VERSION ""

NS_ :

BS_:

BU_: DKY PSC MCR MCL PRG SRM AHL SMT TPM ACN EAM_HUD DAM BIU C_ECU C_ECU_GW

BO_ 948 ACN3B4: 8 ACN
 SG_ ACN3B4_2_0_AMB_AC : 16|13@1+ (0.1,-400) [-400|419.1] "℃"  C_ECU_GW
 SG_ ACN3B4_1_0_MSG_COUNTER : 8|4@1+ (1,0) [0|15] ""  C_ECU_GW
 SG_ ACN3B4_0_0_CHECK_SUM : 0|8@1+ (1,0) [0|255] ""  C_ECU_GW

BO_ 1005 AVN3ED: 8 C_ECU_GW
 SG_ AVN3ED_7_0_ACPANEL_PA_TEMP_DIAL : 58|3@0+ (1,0) [0|7] ""  ACN
 SG_ AVN3ED_7_3_ACPANEL_DR_TEMP_DIAL : 61|3@0+ (1,0) [0|7] ""  ACN
 SG_ AVN3ED_1_0_MSG_COUNTER : 11|4@0+ (1,0) [0|15] ""  ACN
 SG_ AVN3ED_0_0_CHECK_SUM : 7|8@0+ (1,0) [0|255] ""  ACN

BO_ 1723 AVN6BB: 8 C_ECU_GW
 SG_ AVN6BB_7_0_ISA_IACC_OFFSET_CSTM : 56|5@1+ (1,0) [0|20] "" Vector__XXX
 SG_ AVN6BB_7_5_EYE_TOLLBOOTH_DECEL : 61|1@1+ (1,0) [0|1] "" Vector__XXX
 SG_ AVN6BB_7_6_EYE_CURVE_DECEL_CSTM : 62|1@1+ (1,0) [0|1] "" Vector__XXX
 SG_ AVN6BB_7_7_EYE_GREEN_LIGHT_CSTM : 63|1@1+ (1,0) [0|1] "" Vector__XXX
 SG_ AVN6BB_6_0_CCU_FAIL : 48|1@1+ (1,0) [0|1] ""  TPM
 SG_ AVN6BB_6_1_EYE_P_CR_CSTM : 49|1@1+ (1,0) [0|1] "" Vector__XXX
 SG_ AVN6BB_6_2_EYE_ALK_B_LDW_CSTM : 50|2@1+ (1,0) [0|3] "" Vector__XXX
 SG_ AVN6BB_6_4_EYE_CSTM_REQ : 52|1@1+ (1,0) [0|1] "" Vector__XXX
 SG_ AVN6BB_6_5_EYE_ELK_CSTM : 53|1@1+ (1,0) [0|1] "" Vector__XXX
 SG_ AVN6BB_6_6_EYE_ALKB_EDGE_CSTM : 54|1@1+ (1,0) [0|1] "" Vector__XXX
 SG_ AVN6BB_6_7_FCW_ON_OFF : 55|1@1+ (1,0) [0|1] "" Vector__XXX
 SG_ AVN6BB_5_0_DMS_SELECT_ID : 40|4@1+ (1,0) [0|5] "" Vector__XXX
 SG_ AVN6BB_5_4_TPMS_TH_MODE_CSTM : 44|2@1+ (1,0) [0|3] ""  TPM
 SG_ AVN6BB_5_6_DMS_SET_REQ : 46|1@1+ (1,0) [0|1] "" Vector__XXX
 SG_ AVN6BB_5_7_DMS_RECOG_SET : 47|1@1+ (1,0) [0|1] "" Vector__XXX
 SG_ AVN6BB_4_0_DMS_EDIT_REQ : 32|4@1+ (1,0) [0|15] "" Vector__XXX
 SG_ AVN6BB_4_4_VEHICLE_DEMO : 36|1@1+ (1,0) [0|1] "" Vector__XXX
 SG_ AVN6BB_4_5_SRVD_CSTM_REQ : 37|1@1+ (1,0) [0|1] "" Vector__XXX
 SG_ AVN6BB_4_6_SEAT_RESET_REQ : 38|1@1+ (1,0) [0|1] "" Vector__XXX
 SG_ AVN6BB_4_7_SEATAWAY_SET_CSTM : 39|1@1+ (1,0) [0|1] "" Vector__XXX
 SG_ AVN6BB_3_0_SRVD_ON_OFF : 24|1@1+ (1,0) [0|1] "" Vector__XXX
 SG_ AVN6BB_3_1_PRG_RESET_REQ : 25|1@1+ (1,0) [0|1] "" Vector__XXX
 SG_ AVN6BB_3_2_PRG_MEM_CSTM : 26|1@1+ (1,0) [0|1] ""  PRG
 SG_ AVN6BB_3_3_DMS_ON_OFF : 27|1@1+ (1,0) [0|1] "" Vector__XXX
 SG_ AVN6BB_3_4_MIR_RESET_REQ : 28|1@1+ (1,0) [0|1] "" Vector__XXX
 SG_ AVN6BB_3_5_MIR_AFOLD_CSTM : 29|1@1+ (1,0) [0|1] "" Vector__XXX
 SG_ AVN6BB_3_6_MIR_RTILT_CSTM : 30|1@1+ (1,0) [0|1] "" Vector__XXX
 SG_ AVN6BB_3_7_EYE_TSA_CSTM : 31|1@1+ (1,0) [0|1] "" Vector__XXX
 SG_ AVN6BB_2_0_AVH_ON_OFF : 16|2@1+ (1,0) [0|3] "" Vector__XXX
 SG_ AVN6BB_2_2_VDC_ON_OFF : 18|2@1+ (1,0) [0|3] "" Vector__XXX
 SG_ AVN6BB_2_4_CCU_HALT_RESET : 20|1@1+ (1,0) [0|1] ""  TPM
 SG_ AVN6BB_2_5_EYE_LDW_TIMING_CSTM : 21|1@1+ (1,0) [0|1] "" Vector__XXX
 SG_ AVN6BB_2_6_FCW_CSTM : 22|2@1+ (1,0) [0|3] "" Vector__XXX
 SG_ AVN6BB_1_0_MSG_COUNTER : 8|4@1+ (1,0) [0|15] ""  PRG
 SG_ AVN6BB_1_4_EYE_WARN_CSTM : 12|1@1+ (1,0) [0|1] "" Vector__XXX
 SG_ AVN6BB_1_5_EYE_FCTI_CSTM : 13|2@1+ (1,0) [0|3] "" Vector__XXX
 SG_ AVN6BB_1_7_LDW_WARNING_ON_OFF : 15|1@1+ (1,0) [0|1] "" Vector__XXX
 SG_ AVN6BB_0_0_CHECK_SUM : 0|8@1+ (1,0) [0|255] ""  PRG

BO_ 1722 AVN6BA: 8 C_ECU_GW
 SG_ AVN6BA_7_0_GUIDE_LINE_REAR : 56|1@1+ (1,0) [0|1] "" Vector__XXX
 SG_ AVN6BA_7_1_GUIDE_LINE_SIDE : 57|1@1+ (1,0) [0|1] "" Vector__XXX
 SG_ AVN6BA_7_2_GUIDE_LINE_FRONT : 58|1@1+ (1,0) [0|1] "" Vector__XXX
 SG_ AVN6BA_7_3_STEER_ANGLE_INTERLOCK : 59|1@1+ (1,0) [0|1] "" Vector__XXX
 SG_ AVN6BA_7_4_BACK_CAMERA_DELAY : 60|1@1+ (1,0) [0|1] "" Vector__XXX
 SG_ AVN6BA_7_5_REQ_STOP_CAMERA_OUT : 61|1@1+ (1,0) [0|1] "" Vector__XXX
 SG_ AVN6BA_7_6_VIEW_CHANGE_SW : 62|2@1+ (1,0) [0|3] "" Vector__XXX
 SG_ AVN6BA_6_0_CLIMAITE_PA_TEMP : 48|6@1- (0.5,13) [1|44] "℃/?"  ACN
 SG_ AVN6BA_6_6_CLIMATE_SYNC : 54|1@1+ (1,0) [0|1] "" Vector__XXX
 SG_ AVN6BA_6_7_CLIMATE_F_DEF : 55|1@1+ (1,0) [0|1] "" Vector__XXX
 SG_ AVN6BA_5_0_CLIMAITE_DR_TEMP : 40|6@1- (0.5,13) [1|44] "℃/?"  ACN
 SG_ AVN6BA_5_6_CLIMAITE_AUTO : 46|1@1+ (1,0) [0|1] ""  ACN
 SG_ AVN6BA_5_7_CLIMAITE_MAX_AC : 47|1@1+ (1,0) [0|1] ""  ACN
 SG_ AVN6BA_4_0_CLIMAITE_VR : 32|3@1+ (1,0) [0|4] ""  ACN
 SG_ AVN6BA_4_3_CLIMATE_AC : 35|1@1+ (1,0) [0|1] "" Vector__XXX
 SG_ AVN6BA_4_4_CLIMAITE_FAN : 36|4@1+ (1,0) [0|15] ""  ACN
 SG_ AVN6BA_3_0_PERSONAL_IC_SH : 24|3@1+ (1,0) [0|7] "" Vector__XXX
 SG_ AVN6BA_3_4_CSTM_SONNER : 28|1@1+ (1,0) [0|1] "" Vector__XXX
 SG_ AVN6BA_3_5_CSTM_RAB : 29|1@1+ (1,0) [0|1] "" Vector__XXX
 SG_ AVN6BA_3_6_REQ_CHG_CSTM_RAB : 30|1@1+ (1,0) [0|1] "" Vector__XXX
 SG_ AVN6BA_3_7_CLIMATE_R_DEF : 31|1@1+ (1,0) [0|1] "" Vector__XXX
 SG_ AVN6BA_2_0_CLIMATE_PTC : 16|1@1+ (1,0) [0|1] "" Vector__XXX
 SG_ AVN6BA_2_1_CLIMATE_MODE : 17|1@1+ (1,0) [0|1] "" Vector__XXX
 SG_ AVN6BA_2_2_CLIMATE_SEAT_C_L : 18|1@1+ (1,0) [0|1] "" Vector__XXX
 SG_ AVN6BA_2_3_CLIMATE_SEAT_C_R : 19|1@1+ (1,0) [0|1] "" Vector__XXX
 SG_ AVN6BA_2_4_CLIMATE_SEAT_H_L : 20|1@1+ (1,0) [0|1] "" Vector__XXX
 SG_ AVN6BA_2_5_CLIMATE_SEAT_H_R : 21|1@1+ (1,0) [0|1] "" Vector__XXX
 SG_ AVN6BA_2_6_CLIMATE_INNER_AIR : 22|1@1+ (1,0) [0|1] "" Vector__XXX
 SG_ AVN6BA_2_7_CLIMATE_ON_OFF : 23|1@1+ (1,0) [0|1] "" Vector__XXX
 SG_ AVN6BA_1_0_MSG_COUNTER : 8|4@1+ (1,0) [0|15] ""  ACN
 SG_ AVN6BA_1_4_CLIMAITE_STATUS : 12|3@1+ (1,0) [0|7] "" Vector__XXX
 SG_ AVN6BA_1_7_CLIMAITE_ON_OFF : 15|1@1+ (1,0) [0|1] "" Vector__XXX
 SG_ AVN6BA_0_0_CHECK_SUM : 0|8@1+ (1,0) [0|255] ""  ACN

BO_ 1019 AVN3FB: 8 C_ECU_GW
 SG_ AVN3FB_7_0_SMT_TIM_RESET_REQ : 56|1@1+ (1,0) [0|1] "" Vector__XXX
 SG_ AVN3FB_7_1_SMT_EG_CSTM_REQ : 57|1@1+ (1,0) [0|1] "" Vector__XXX
 SG_ AVN3FB_7_2_EYE_YEILD_CSTM : 58|1@1+ (1,0) [0|1] "" Vector__XXX
 SG_ AVN3FB_7_3_EYE_STOP_CSTM : 59|1@1+ (1,0) [0|1] "" Vector__XXX
 SG_ AVN3FB_7_4_EYE_NO_ENTRY_CSTM : 60|1@1+ (1,0) [0|1] "" Vector__XXX
 SG_ AVN3FB_7_5_MVS_CAMERA_SELECT_SW : 61|1@1+ (1,0) [0|1] "" Vector__XXX
 SG_ AVN3FB_7_7_ACPANEL_DR_ONLY : 63|1@1+ (1,0) [0|1] ""  ACN
 SG_ AVN3FB_6_0_ACPANEL_PA_TEMP : 48|6@1+ (0.5,13) [1|44] "℃/?"  ACN
 SG_ AVN3FB_6_6_ACPANEL_MODE_DOWN : 54|1@1+ (1,0) [0|1] ""  ACN
 SG_ AVN3FB_6_7_ACPANEL_MODE_UP : 55|1@1+ (1,0) [0|1] ""  ACN
 SG_ AVN3FB_5_0_ACPANEL_DR_TEMP : 40|6@1+ (0.5,13) [1|44] "℃/?"  ACN
 SG_ AVN3FB_5_6_ACPANEL_FAN_DOWN : 46|1@1+ (1,0) [0|1] ""  ACN
 SG_ AVN3FB_5_7_ACPANEL_FAN_UP : 47|1@1+ (1,0) [0|1] ""  ACN
 SG_ AVN3FB_4_0_ACPANEL_FAN_LEVEL : 32|4@1+ (1,0) [0|15] ""  ACN
 SG_ AVN3FB_4_4_ACPANEL_MODE_VENT : 36|4@1+ (1,0) [0|15] ""  ACN
 SG_ AVN3FB_3_0_ACPANEL_PA_TEMP_DOWN : 24|1@1+ (1,0) [0|1] ""  ACN
 SG_ AVN3FB_3_1_ACPANEL_PA_TEMP_UP : 25|1@1+ (1,0) [0|1] ""  ACN
 SG_ AVN3FB_3_2_ACPANEL_DR_TEMP_DOWN : 26|1@1+ (1,0) [0|1] ""  ACN
 SG_ AVN3FB_3_3_ACPANEL_DR_TEMP_UP : 27|1@1+ (1,0) [0|1] ""  ACN
 SG_ AVN3FB_3_4_ACPANEL_SYNC : 28|1@1+ (1,0) [0|1] ""  ACN
 SG_ AVN3FB_3_5_ACPANEL_AC : 29|1@1+ (1,0) [0|1] ""  ACN
 SG_ AVN3FB_3_6_F_DEF_SW : 30|1@1+ (1,0) [0|1] ""  ACN
 SG_ AVN3FB_3_7_R_DEF_SW : 31|1@1+ (1,0) [0|1] ""  ACN
 SG_ AVN3FB_2_0_ACPANEL_AUTO : 16|1@1+ (1,0) [0|1] ""  ACN
 SG_ AVN3FB_2_1_ACPANEL_MAX_AC : 17|1@1+ (1,0) [0|1] ""  ACN
 SG_ AVN3FB_2_2_ACPANEL_SEAT_C_P : 18|1@1+ (1,0) [0|1] ""  ACN
 SG_ AVN3FB_2_3_ACPANEL_SEAT_C_D : 19|1@1+ (1,0) [0|1] ""  ACN
 SG_ AVN3FB_2_4_ACPANEL_SEAT_H_P : 20|1@1+ (1,0) [0|1] ""  ACN
 SG_ AVN3FB_2_5_ACPANEL_SEAT_H_D : 21|1@1+ (1,0) [0|1] ""  ACN
 SG_ AVN3FB_2_6_ACPANEL_INNER_AIR : 22|1@1+ (1,0) [0|1] ""  ACN
 SG_ AVN3FB_2_7_ACPANEL_AC_ON_OFF : 23|1@1+ (1,0) [0|1] ""  ACN
 SG_ AVN3FB_1_0_MSG_COUNTER : 8|4@1+ (1,0) [0|15] ""  ACN
 SG_ AVN3FB_1_4_EYE_CSTM_REQ_3FB : 12|1@1+ (1,0) [0|1] "" Vector__XXX
 SG_ AVN3FB_1_5_DDAW_WARNING_CSTM : 13|1@1+ (1,0) [0|1] "" Vector__XXX
 SG_ AVN3FB_1_6_SIGN_SWITCH_SND : 14|1@1+ (1,0) [0|1] "" Vector__XXX
 SG_ AVN3FB_1_7_SLWF_CSTM : 15|1@1+ (1,0) [0|1] "" Vector__XXX
 SG_ AVN3FB_0_0_CHECK_SUM : 0|8@1+ (1,0) [0|255] ""  ACN

BO_ 1767 RES6E7: 8 C_ECU_GW
 SG_ RES6E7_2_0_DATA2 : 16|48@1+ (1,0) [0|281474976700000] "" Vector__XXX
 SG_ RES6E7_1_0_MSG_COUNTER : 8|4@1+ (1,0) [0|15] "" Vector__XXX
 SG_ RES6E7_1_4_DATA1 : 12|4@1+ (1,0) [0|15] "" Vector__XXX
 SG_ RES6E7_0_0_CHECK_SUM : 0|8@1+ (1,0) [0|255] "" Vector__XXX

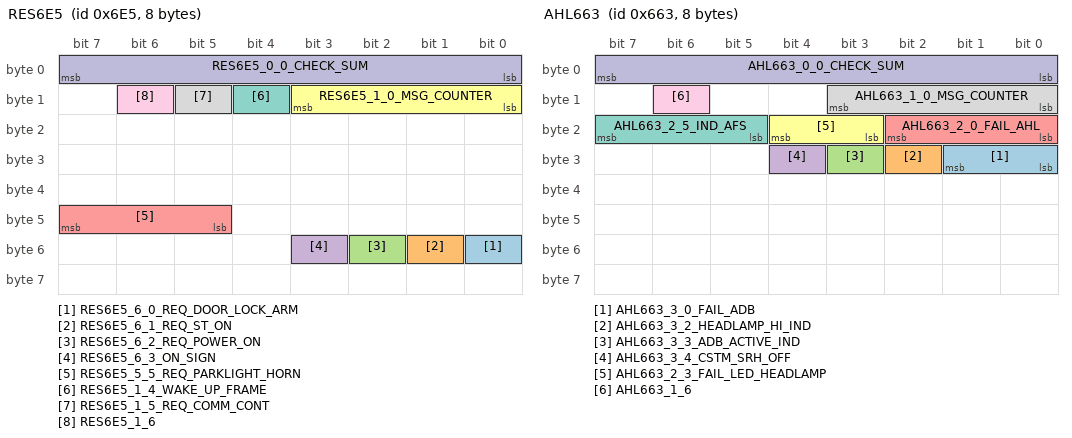
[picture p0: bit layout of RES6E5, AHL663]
BO_ 1765 RES6E5: 8 C_ECU_GW
 SG_ RES6E5_6_0_REQ_DOOR_LOCK_ARM : 48|1@1+ (1,0) [0|1] "" Vector__XXX
 SG_ RES6E5_6_1_REQ_ST_ON : 49|1@1+ (1,0) [0|1] ""  BIU
 SG_ RES6E5_6_2_REQ_POWER_ON : 50|1@1+ (1,0) [0|1] "" Vector__XXX
 SG_ RES6E5_6_3_ON_SIGN : 51|1@1+ (1,0) [0|1] ""  ACN,BIU
 SG_ RES6E5_5_5_REQ_PARKLIGHT_HORN : 45|3@1+ (1,0) [0|4] ""  BIU
 SG_ RES6E5_1_0_MSG_COUNTER : 8|4@1+ (1,0) [0|15] ""  BIU
 SG_ RES6E5_1_4_WAKE_UP_FRAME : 12|1@1+ (1,0) [0|1] "" Vector__XXX
 SG_ RES6E5_1_5_REQ_COMM_CONT : 13|1@1+ (1,0) [0|1] "" Vector__XXX
 SG_ RES6E5_1_6 : 14|1@1+ (1,0) [0|1] "" Vector__XXX
 SG_ RES6E5_0_0_CHECK_SUM : 0|8@1+ (1,0) [0|255] ""  BIU

BO_ 1635 AHL663: 8 AHL
 SG_ AHL663_3_0_FAIL_ADB : 24|2@1+ (1,0) [0|3] ""  C_ECU_GW
 SG_ AHL663_3_2_HEADLAMP_HI_IND : 26|1@1+ (1,0) [0|1] ""  C_ECU_GW
 SG_ AHL663_3_3_ADB_ACTIVE_IND : 27|1@1+ (1,0) [0|1] ""  C_ECU_GW
 SG_ AHL663_3_4_CSTM_SRH_OFF : 28|1@1+ (1,0) [0|1] ""  C_ECU_GW
 SG_ AHL663_2_0_FAIL_AHL : 16|3@1+ (1,0) [0|7] ""  C_ECU_GW
 SG_ AHL663_2_3_FAIL_LED_HEADLAMP : 19|2@1+ (1,0) [0|3] ""  C_ECU_GW
 SG_ AHL663_2_5_IND_AFS : 21|3@1+ (1,0) [0|7] ""  C_ECU_GW
 SG_ AHL663_1_0_MSG_COUNTER : 8|4@1+ (1,0) [0|15] ""  C_ECU_GW
 SG_ AHL663_1_6 : 14|1@1+ (1,0) [0|1] ""  C_ECU_GW
 SG_ AHL663_0_0_CHECK_SUM : 0|8@1+ (1,0) [0|255] ""  C_ECU_GW

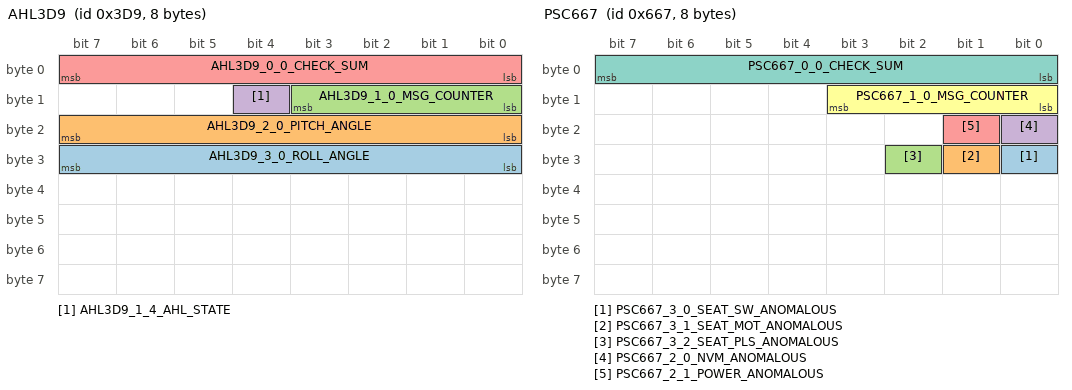
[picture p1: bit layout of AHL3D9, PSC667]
BO_ 985 AHL3D9: 8 AHL
 SG_ AHL3D9_3_0_ROLL_ANGLE : 24|8@1- (1,0) [-65|65] "deg"  C_ECU_GW
 SG_ AHL3D9_2_0_PITCH_ANGLE : 16|8@1- (1,0) [-65|65] "deg"  C_ECU_GW
 SG_ AHL3D9_1_0_MSG_COUNTER : 8|4@1+ (1,0) [0|15] ""  C_ECU_GW
 SG_ AHL3D9_1_4_AHL_STATE : 12|1@1+ (1,0) [0|1] ""  C_ECU_GW
 SG_ AHL3D9_0_0_CHECK_SUM : 0|8@1+ (1,0) [0|255] ""  C_ECU_GW

BO_ 1363 AHL553: 8 AHL
 SG_ AHL553_7_0_NETWORK_STATUS : 7|64@0+ (1,0) [0|0] ""  C_ECU

BO_ 1631 IMB65F: 8 SMT
 SG_ IMB65F_2_0_DATA2 : 16|48@1+ (1,0) [0|281474976710660] ""  C_ECU_GW
 SG_ IMB65F_1_0_MSG_COUNTER : 8|4@1+ (1,0) [0|15] ""  C_ECU_GW
 SG_ IMB65F_1_4_DATA1 : 12|4@1+ (1,0) [0|15] ""  C_ECU_GW
 SG_ IMB65F_0_0_CHECK_SUM : 0|8@1+ (1,0) [0|255] ""  C_ECU_GW

BO_ 1296 PSM510: 8 PSC
 SG_ PSM510_1_4_ActiveWakeUpBit : 12|1@1+ (1,0) [0|1] ""  MCR,MCL,PRG,SMT,TPM,BIU,C_ECU
 SG_ PSM510_0_0_SourceNodeID : 0|8@1+ (1,0) [0|255] ""  MCR,MCL,PRG,SMT,TPM,BIU,C_ECU

BO_ 1639 PSC667: 8 PSC
 SG_ PSC667_3_0_SEAT_SW_ANOMALOUS : 24|1@0+ (1,0) [0|1] ""  C_ECU
 SG_ PSC667_3_1_SEAT_MOT_ANOMALOUS : 25|1@0+ (1,0) [0|1] ""  C_ECU
 SG_ PSC667_3_2_SEAT_PLS_ANOMALOUS : 26|1@0+ (1,0) [0|1] ""  C_ECU
 SG_ PSC667_2_0_NVM_ANOMALOUS : 16|1@0+ (1,0) [0|1] ""  C_ECU
 SG_ PSC667_2_1_POWER_ANOMALOUS : 17|1@0+ (1,0) [0|1] ""  C_ECU
 SG_ PSC667_1_0_MSG_COUNTER : 11|4@0+ (1,0) [0|15] ""  C_ECU
 SG_ PSC667_0_0_CHECK_SUM : 7|8@0+ (1,0) [0|255] ""  C_ECU

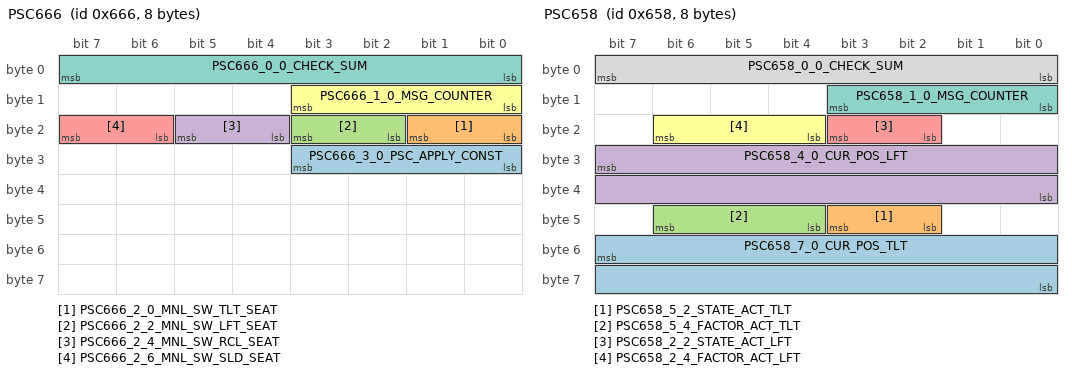
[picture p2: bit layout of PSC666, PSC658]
BO_ 1638 PSC666: 8 PSC
 SG_ PSC666_3_0_PSC_APPLY_CONST : 27|4@0+ (1,0) [0|7] ""  C_ECU
 SG_ PSC666_2_0_MNL_SW_TLT_SEAT : 17|2@0+ (1,0) [0|3] ""  C_ECU
 SG_ PSC666_2_2_MNL_SW_LFT_SEAT : 19|2@0+ (1,0) [0|3] ""  C_ECU
 SG_ PSC666_2_4_MNL_SW_RCL_SEAT : 21|2@0+ (1,0) [0|3] ""  C_ECU
 SG_ PSC666_2_6_MNL_SW_SLD_SEAT : 23|2@0+ (1,0) [0|3] ""  C_ECU
 SG_ PSC666_1_0_MSG_COUNTER : 11|4@0+ (1,0) [0|15] ""  C_ECU
 SG_ PSC666_0_0_CHECK_SUM : 7|8@0+ (1,0) [0|255] ""  C_ECU

BO_ 1624 PSC658: 8 PSC
 SG_ PSC658_7_0_CUR_POS_TLT : 55|16@0+ (1,0) [0|65535] "count"  C_ECU
 SG_ PSC658_5_2_STATE_ACT_TLT : 43|2@0+ (1,0) [0|3] ""  C_ECU
 SG_ PSC658_5_4_FACTOR_ACT_TLT : 46|3@0+ (1,0) [0|3] ""  C_ECU
 SG_ PSC658_4_0_CUR_POS_LFT : 31|16@0+ (1,0) [0|65535] "count"  C_ECU
 SG_ PSC658_2_2_STATE_ACT_LFT : 19|2@0+ (1,0) [0|3] ""  C_ECU
 SG_ PSC658_2_4_FACTOR_ACT_LFT : 22|3@0+ (1,0) [0|3] ""  C_ECU
 SG_ PSC658_1_0_MSG_COUNTER : 11|4@0+ (1,0) [0|15] ""  C_ECU
 SG_ PSC658_0_0_CHECK_SUM : 7|8@0+ (1,0) [0|255] ""  C_ECU

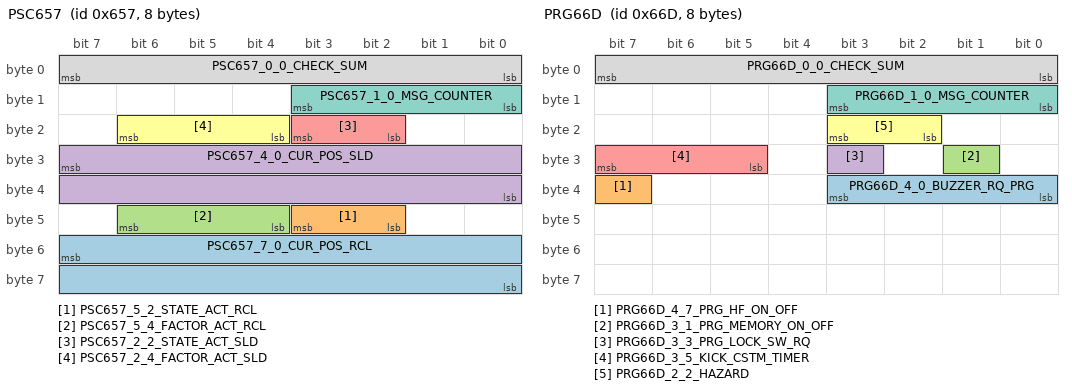
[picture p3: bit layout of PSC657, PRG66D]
BO_ 1623 PSC657: 8 PSC
 SG_ PSC657_7_0_CUR_POS_RCL : 55|16@0+ (1,0) [0|65535] "count"  C_ECU
 SG_ PSC657_5_2_STATE_ACT_RCL : 43|2@0+ (1,0) [0|3] ""  C_ECU
 SG_ PSC657_5_4_FACTOR_ACT_RCL : 46|3@0+ (1,0) [0|3] ""  C_ECU
 SG_ PSC657_4_0_CUR_POS_SLD : 31|16@0+ (1,0) [0|65535] "count"  C_ECU
 SG_ PSC657_2_2_STATE_ACT_SLD : 19|2@0+ (1,0) [0|3] ""  C_ECU
 SG_ PSC657_2_4_FACTOR_ACT_SLD : 22|3@0+ (1,0) [0|3] ""  C_ECU
 SG_ PSC657_1_0_MSG_COUNTER : 11|4@0+ (1,0) [0|15] ""  C_ECU
 SG_ PSC657_0_0_CHECK_SUM : 7|8@0+ (1,0) [0|255] ""  C_ECU

BO_ 1661 MEP67D: 8 Vector__XXX

BO_ 1298 MEP512: 8 MCR
 SG_ MEP512_1_4_ActiveWakeUpBit : 12|1@1+ (1,0) [0|1] ""  PSC,MCL,PRG,SMT,TPM,BIU,C_ECU
 SG_ MEP512_0_0_SourceNodeID : 0|8@1+ (1,0) [0|255] ""  PSC,MCL,PRG,SMT,TPM,BIU,C_ECU

BO_ 1662 MED67E: 8 Vector__XXX

BO_ 1297 MED511: 8 MCL
 SG_ MED511_1_4_ActiveWakeUpBit : 12|1@1+ (1,0) [0|1] ""  PSC,MCR,PRG,SMT,TPM,BIU,C_ECU
 SG_ MED511_0_0_SourceNodeID : 0|8@1+ (1,0) [0|255] ""  PSC,MCR,PRG,SMT,TPM,BIU,C_ECU

BO_ 1645 PRG66D: 8 C_ECU
 SG_ PRG66D_4_0_BUZZER_RQ_PRG : 32|4@1+ (1,0) [0|15] ""  DAM
 SG_ PRG66D_4_7_PRG_HF_ON_OFF : 39|1@1+ (1,0) [0|1] ""  SMT
 SG_ PRG66D_3_1_PRG_MEMORY_ON_OFF : 25|1@1+ (1,0) [0|1] "" Vector__XXX
 SG_ PRG66D_3_3_PRG_LOCK_SW_RQ : 27|1@1+ (1,0) [0|1] ""  SMT
 SG_ PRG66D_3_5_KICK_CSTM_TIMER : 29|3@1+ (1,0) [0|7] ""  DAM
 SG_ PRG66D_2_2_HAZARD : 18|2@1+ (1,0) [0|3] ""  BIU
 SG_ PRG66D_1_0_MSG_COUNTER : 8|4@1+ (1,0) [0|15] ""  SMT,BIU
 SG_ PRG66D_0_0_CHECK_SUM : 0|8@1+ (1,0) [0|255] ""  SMT,BIU

BO_ 1294 PRG50E: 8 PRG
 SG_ PRG50E_1_4_ActiveWakeUpBit : 12|1@1+ (1,0) [0|1] ""  PSC,MCR,MCL,SMT,TPM,BIU,C_ECU
 SG_ PRG50E_0_0_SourceNodeID : 0|8@1+ (1,0) [0|255] ""  PSC,MCR,MCL,SMT,TPM,BIU,C_ECU

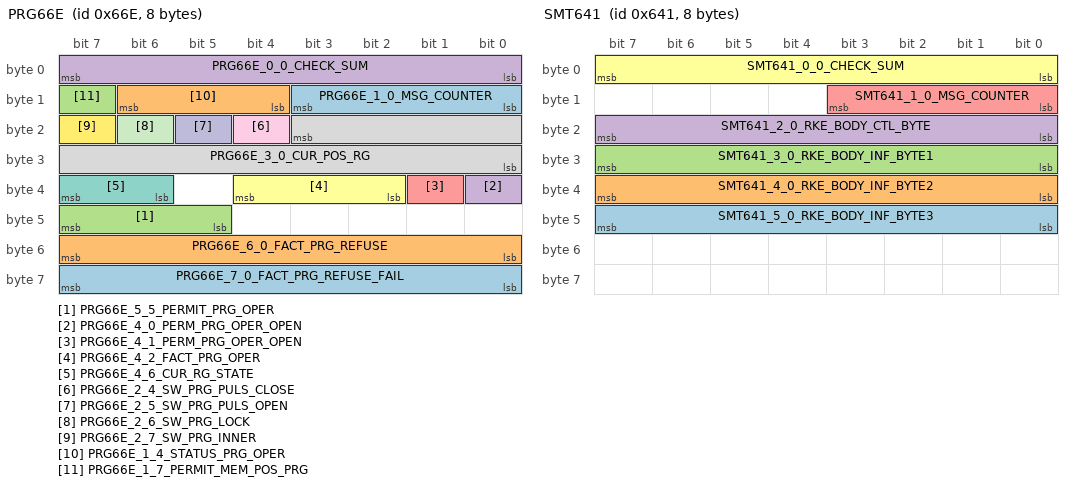
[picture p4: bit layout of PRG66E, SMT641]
BO_ 1646 PRG66E: 8 PRG
 SG_ PRG66E_7_0_FACT_PRG_REFUSE_FAIL : 63|8@0+ (1,0) [0|255] ""  C_ECU,C_ECU_GW
 SG_ PRG66E_6_0_FACT_PRG_REFUSE : 55|8@0+ (1,0) [0|255] ""  C_ECU,C_ECU_GW
 SG_ PRG66E_5_5_PERMIT_PRG_OPER : 47|3@0+ (1,0) [0|7] ""  C_ECU,C_ECU_GW
 SG_ PRG66E_4_0_PERM_PRG_OPER_OPEN : 32|1@0+ (1,0) [0|1] ""  C_ECU,C_ECU_GW
 SG_ PRG66E_4_1_PERM_PRG_OPER_OPEN : 33|1@0+ (1,0) [0|1] ""  C_ECU,C_ECU_GW
 SG_ PRG66E_4_2_FACT_PRG_OPER : 36|3@0+ (1,0) [0|7] ""  C_ECU,C_ECU_GW
 SG_ PRG66E_4_6_CUR_RG_STATE : 39|2@0+ (1,0) [0|3] ""  C_ECU,C_ECU_GW
 SG_ PRG66E_3_0_CUR_POS_RG : 19|12@0+ (1,0) [0|4095] ""  C_ECU,C_ECU_GW
 SG_ PRG66E_2_4_SW_PRG_PULS_CLOSE : 20|1@0+ (1,0) [0|1] ""  C_ECU,C_ECU_GW
 SG_ PRG66E_2_5_SW_PRG_PULS_OPEN : 21|1@0+ (1,0) [0|1] ""  C_ECU,C_ECU_GW
 SG_ PRG66E_2_6_SW_PRG_LOCK : 22|1@0+ (1,0) [0|1] ""  C_ECU,C_ECU_GW
 SG_ PRG66E_2_7_SW_PRG_INNER : 23|1@0+ (1,0) [0|1] ""  C_ECU,C_ECU_GW
 SG_ PRG66E_1_0_MSG_COUNTER : 11|4@0+ (1,0) [0|15] ""  SMT,BIU,C_ECU,C_ECU_GW
 SG_ PRG66E_1_4_STATUS_PRG_OPER : 14|3@0+ (1,0) [0|7] ""  SMT,BIU,C_ECU,C_ECU_GW
 SG_ PRG66E_1_7_PERMIT_MEM_POS_PRG : 15|1@0+ (1,0) [0|1] ""  C_ECU,C_ECU_GW
 SG_ PRG66E_0_0_CHECK_SUM : 7|8@0+ (1,0) [0|255] ""  SMT,BIU,C_ECU,C_ECU_GW

BO_ 1628 PRG65C: 8 PRG
 SG_ PRG65C_3_0_FLAG_PRG_FAIL_B : 31|8@0+ (1,0) [0|255] ""  C_ECU
 SG_ PRG65C_2_0_FLAG_PRG_FAIL_A : 23|8@0+ (1,0) [0|255] ""  C_ECU
 SG_ PRG65C_1_0_MSG_COUNTER : 11|4@0+ (1,0) [0|15] ""  C_ECU
 SG_ PRG65C_0_0_CHECK_SUM : 7|8@0+ (1,0) [0|255] ""  C_ECU

BO_ 818 PMN332: 8 SMT
 SG_ PMN332_7_0_RES_CONTROL_STATUS : 56|2@1+ (1,0) [0|3] ""  C_ECU_GW
 SG_ PMN332_7_2_REQ_RES_P_LOCK : 58|1@1+ (1,0) [0|1] ""  BIU,C_ECU_GW
 SG_ PMN332_7_5_IGB_RELAY_REQ : 61|1@1+ (1,0) [0|1] ""  C_ECU_GW
 SG_ PMN332_7_6_IGA_RELAY_REQ : 62|1@1+ (1,0) [0|1] ""  C_ECU_GW
 SG_ PMN332_7_7_REQ_STOP_RES : 63|1@1+ (1,0) [0|1] ""  C_ECU_GW
 SG_ PMN332_6_0_RES_IDLE_TIME : 48|7@1+ (10,0) [0|1270] "sec"  C_ECU_GW
 SG_ PMN332_6_7_CUST : 55|1@1+ (1,0) [0|1] ""  C_ECU_GW
 SG_ PMN332_5_0_PUSHSTART_SW : 40|1@1+ (1,0) [0|1] ""  C_ECU_GW
 SG_ PMN332_5_1_SIG_KEY_PUSHSTART : 41|1@1+ (1,0) [0|1] ""  BIU,C_ECU_GW
 SG_ PMN332_5_2_STATE_MODE_POWER : 42|2@1+ (1,0) [0|2] ""  BIU,C_ECU_GW
 SG_ PMN332_5_4_BUZ_2SHOT_IN : 44|1@1+ (1,0) [0|1] ""  C_ECU_GW
 SG_ PMN332_5_5_BUZ_INTERMIT1_IN : 45|1@1+ (1,0) [0|1] ""  C_ECU_GW
 SG_ PMN332_5_6_BUZ_INTERMIT2_IN : 46|1@1+ (1,0) [0|1] ""  C_ECU_GW
 SG_ PMN332_5_7_BUZ_CONTINUE_IN : 47|1@1+ (1,0) [0|1] ""  C_ECU_GW
 SG_ PMN332_2_0_WARN_SSP_SIG1 : 16|1@1+ (1,0) [0|1] ""  C_ECU_GW
 SG_ PMN332_2_1_WARN_SSP_SIG2 : 17|3@1+ (1,0) [0|4] ""  C_ECU_GW
 SG_ PMN332_2_4_SMT_PWR_SIG : 20|2@1+ (1,0) [0|2] ""  C_ECU_GW
 SG_ PMN332_2_7_BUZ_1SHOT_IN : 23|1@1+ (1,0) [0|1] ""  C_ECU_GW
 SG_ PMN332_1_0_MSG_COUNTER : 8|4@1+ (1,0) [0|15] ""  BIU,C_ECU_GW
 SG_ PMN332_0_0_CHECK_SUM : 0|8@1+ (1,0) [0|255] ""  BIU,C_ECU_GW

BO_ 1303 PMN517: 8 SMT
 SG_ PMN517_1_4_ActiveWakeUpBit : 12|1@1+ (1,0) [0|1] ""  PSC,MCR,MCL,PRG,BIU,C_ECU
 SG_ PMN517_0_0_SourceNodeID : 0|8@1+ (1,0) [0|255] ""  PSC,MCR,MCL,PRG,BIU,C_ECU

BO_ 1603 SMT643: 8 Vector__XXX
 SG_ SMT643_2_0_DATA2 : 16|48@1+ (1,0) [0|281474976700000] ""  C_ECU_GW
 SG_ SMT643_1_0_MSG_COUNTER : 8|4@1+ (1,0) [0|15] ""  C_ECU_GW
 SG_ SMT643_1_4_DATA1 : 12|4@1+ (1,0) [0|15] ""  C_ECU_GW
 SG_ SMT643_0_0_CHECK_SUM : 0|8@1+ (1,0) [0|255] ""  C_ECU_GW

BO_ 1601 SMT641: 8 SMT
 SG_ SMT641_5_0_RKE_BODY_INF_BYTE3 : 40|8@1+ (1,0) [0|255] ""  BIU,C_ECU_GW
 SG_ SMT641_4_0_RKE_BODY_INF_BYTE2 : 32|8@1+ (1,0) [0|255] ""  BIU,C_ECU_GW
 SG_ SMT641_3_0_RKE_BODY_INF_BYTE1 : 24|8@1+ (1,0) [0|255] ""  BIU,C_ECU_GW
 SG_ SMT641_2_0_RKE_BODY_CTL_BYTE : 16|8@1+ (1,0) [0|255] ""  BIU,C_ECU_GW
 SG_ SMT641_1_0_MSG_COUNTER : 8|4@1+ (1,0) [0|15] ""  BIU,C_ECU_GW
 SG_ SMT641_0_0_CHECK_SUM : 0|8@1+ (1,0) [0|255] ""  BIU,C_ECU_GW

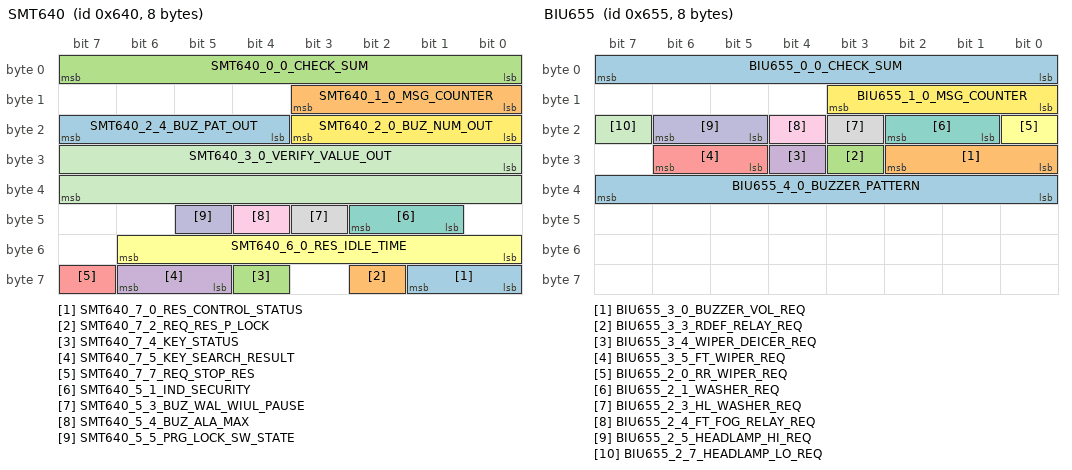
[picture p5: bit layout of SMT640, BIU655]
BO_ 1600 SMT640: 8 SMT
 SG_ SMT640_7_0_RES_CONTROL_STATUS : 56|2@1+ (1,0) [0|3] ""  C_ECU_GW
 SG_ SMT640_7_2_REQ_RES_P_LOCK : 58|1@1+ (1,0) [0|1] ""  C_ECU_GW
 SG_ SMT640_7_4_KEY_STATUS : 60|1@1+ (1,0) [0|1] ""  BIU,C_ECU_GW
 SG_ SMT640_7_5_KEY_SEARCH_RESULT : 61|2@1+ (1,0) [0|3] ""  C_ECU,C_ECU_GW
 SG_ SMT640_7_7_REQ_STOP_RES : 63|1@1+ (1,0) [0|1] ""  C_ECU_GW
 SG_ SMT640_6_0_RES_IDLE_TIME : 48|7@1+ (1,0) [0|1200] "sec"  C_ECU_GW
 SG_ SMT640_5_1_IND_SECURITY : 41|2@1+ (1,0) [0|3] ""  BIU,C_ECU_GW
 SG_ SMT640_5_3_BUZ_WAL_WIUL_PAUSE : 43|1@1+ (1,0) [0|1] ""  BIU,C_ECU_GW
 SG_ SMT640_5_4_BUZ_ALA_MAX : 44|1@1+ (1,0) [0|1] ""  C_ECU_GW
 SG_ SMT640_5_5_PRG_LOCK_SW_STATE : 45|1@1+ (1,0) [0|1] ""  C_ECU_GW
 SG_ SMT640_3_0_VERIFY_VALUE_OUT : 24|16@1+ (1,0) [0|65535] ""  BIU,C_ECU,C_ECU_GW
 SG_ SMT640_2_0_BUZ_NUM_OUT : 16|4@1+ (1,0) [0|15] ""  BIU,C_ECU_GW
 SG_ SMT640_2_4_BUZ_PAT_OUT : 20|4@1+ (1,0) [0|15] ""  BIU,C_ECU_GW
 SG_ SMT640_1_0_MSG_COUNTER : 8|4@1+ (1,0) [0|15] ""  BIU,C_ECU,C_ECU_GW
 SG_ SMT640_0_0_CHECK_SUM : 0|8@1+ (1,0) [0|255] ""  BIU,C_ECU,C_ECU_GW

BO_ 816 SMT330: 8 SMT
 SG_ SMT330_7_0 : 56|1@1+ (1,0) [0|1] ""  C_ECU_GW
 SG_ SMT330_7_1 : 57|1@1+ (1,0) [0|1] ""  C_ECU_GW
 SG_ SMT330_7_3_HF_CAPA_ERR_ST : 59|1@1+ (1,0) [0|1] ""  C_ECU,C_ECU_GW
 SG_ SMT330_7_6_HF_RESP_ERR_ST : 62|1@1+ (1,0) [0|1] ""  C_ECU_GW
 SG_ SMT330_6_0_REQ_MESS_PUSHSTART : 48|4@1+ (1,0) [0|8] ""  C_ECU_GW
 SG_ SMT330_6_4_WARN_SSP_SIG1 : 52|4@1+ (1,0) [0|14] ""  C_ECU_GW
 SG_ SMT330_5_1_WIUL_CUST : 41|1@1+ (1,0) [0|1] ""  DKY,C_ECU_GW
 SG_ SMT330_5_2_WAL_CUST : 42|1@1+ (1,0) [0|1] ""  DKY,C_ECU_GW
 SG_ SMT330_5_3_WARN_SSP_SIG2 : 43|2@1+ (1,0) [0|2] ""  C_ECU_GW
 SG_ SMT330_5_5_WARN_SSP_SIG3 : 45|3@1+ (1,0) [0|4] ""  C_ECU_GW
 SG_ SMT330_4_0_PUSHSTART_SW : 32|1@1+ (1,0) [0|1] ""  C_ECU_GW
 SG_ SMT330_4_1_SIG_KEY_PUSHSTART : 33|1@1+ (1,0) [0|1] ""  C_ECU_GW
 SG_ SMT330_4_2_HF_TOUCH_STATUS : 34|3@1+ (1,0) [0|7] ""  C_ECU_GW
 SG_ SMT330_4_5_HF_KICK_STATUS : 37|2@1+ (1,0) [0|17] ""  BIU,C_ECU_GW
 SG_ SMT330_3_0_BUZ_1SHOT_IN : 24|1@1+ (1,0) [0|1] ""  C_ECU_GW
 SG_ SMT330_3_1_BUZ_2SHOT_IN : 25|1@1+ (1,0) [0|1] ""  C_ECU_GW
 SG_ SMT330_3_2_BUZ_INTERMIT1_IN : 26|1@1+ (1,0) [0|1] ""  C_ECU_GW
 SG_ SMT330_3_3_BUZ_INTERMIT2_IN : 27|1@1+ (1,0) [0|1] ""  C_ECU_GW
 SG_ SMT330_3_4_BUZ_CONTINUE_IN : 28|1@1+ (1,0) [0|1] ""  C_ECU_GW
 SG_ SMT330_3_5_BUZ_TRPON_OK_IN : 29|1@1+ (1,0) [0|1] ""  C_ECU_GW
 SG_ SMT330_3_6_STATE_MODE_POWER : 30|2@1+ (1,0) [0|2] ""  C_ECU_GW
 SG_ SMT330_1_0_MSG_COUNTER : 8|4@1+ (1,0) [0|15] ""  DKY,C_ECU,C_ECU_GW
 SG_ SMT330_1_4_WAKE_UP_FRAME : 12|1@1+ (1,0) [0|1] ""  C_ECU_GW
 SG_ SMT330_1_5_REQ_COMM_CONT : 13|1@1+ (1,0) [0|1] ""  C_ECU_GW
 SG_ SMT330_1_6 : 14|1@1+ (1,0) [0|1] ""  C_ECU_GW
 SG_ SMT330_0_0_CHECK_SUM : 0|8@1+ (1,0) [0|255] ""  DKY,BIU,C_ECU,C_ECU_GW

BO_ 1289 SMT509: 8 SMT
 SG_ SMT509_1_4_ActiveWakeUpBit : 12|1@1+ (1,0) [0|1] ""  PSC,MCR,MCL,PRG,BIU,C_ECU
 SG_ SMT509_0_0_SourceNodeID : 0|8@1+ (1,0) [0|255] ""  PSC,MCR,MCL,PRG,BIU,C_ECU

BO_ 1759 BIU6DF: 8 BIU
 SG_ BIU6DF_2_1_ALARM_DATA : 17|2@1+ (1,0) [0|1] "" Vector__XXX
 SG_ BIU6DF_1_1_DATA : 9|2@1+ (1,0) [0|1] "" Vector__XXX

BO_ 1622 BIU656: 8 BIU
 SG_ BIU656_6_0_KICK_OPEN_REQ_PRG : 48|1@1+ (1,0) [0|1] ""  C_ECU_GW
 SG_ BIU656_6_1_KICK_CLOSE_REQ_PRG : 49|1@1+ (1,0) [0|1] ""  C_ECU_GW
 SG_ BIU656_6_6_CARGO_LAMP_OUT : 54|1@1+ (1,0) [0|1] ""  PRG,C_ECU_GW
 SG_ BIU656_6_7_PERMITT_KEY_RG_UNL : 55|1@1+ (1,0) [0|1] ""  C_ECU,C_ECU_GW
 SG_ BIU656_5_0_PRG_DRVR_OPENERSW : 40|1@1+ (1,0) [0|1] ""  C_ECU_GW
 SG_ BIU656_5_1_HF_PRG_OFF_SW : 41|1@1+ (1,0) [0|1] ""  C_ECU_GW
 SG_ BIU656_5_2_PERMIT_OPEN_RG : 42|1@1+ (1,0) [0|1] ""  C_ECU,C_ECU_GW
 SG_ BIU656_5_3_BUZ_ON_OFF : 43|1@1+ (1,0) [0|1] ""  C_ECU,C_ECU_GW
 SG_ BIU656_5_4_PRG_DRVR_SW_PERMIT : 44|1@1+ (1,0) [0|1] ""  C_ECU,C_ECU_GW
 SG_ BIU656_5_5_CSTM_HF_PRG_LOCK : 45|1@1+ (1,0) [0|1] ""  SMT,C_ECU_GW
 SG_ BIU656_5_6_CSTM_KICK_SENSOR : 46|1@1+ (1,0) [0|1] ""  SMT,C_ECU_GW
 SG_ BIU656_5_7_KICK_REQ_PRG : 47|1@1+ (1,0) [0|1] ""  C_ECU,C_ECU_GW
 SG_ BIU656_4_0_NOT_SMT_KEY_RG_SW : 32|2@1+ (1,0) [0|3] ""  C_ECU_GW
 SG_ BIU656_4_2_SMT_KEY_RG_SW : 34|2@1+ (1,0) [0|3] ""  C_ECU,C_ECU_GW
 SG_ BIU656_4_4_OPEN_RG_OPENER_SW : 36|2@1+ (1,0) [0|3] ""  C_ECU,C_ECU_GW
 SG_ BIU656_3_4_CHECKED_KEYNO : 28|3@1+ (1,0) [0|7] ""  C_ECU_GW
 SG_ BIU656_3_7_LOCKSTATUS_DRVR : 31|1@1+ (1,0) [0|1] ""  C_ECU_GW
 SG_ BIU656_2_0_TRIG_LOCK_UNLOCK : 16|12@1+ (1,0) [0|4095] ""  C_ECU,C_ECU_GW
 SG_ BIU656_1_0_MSG_COUNTER : 8|4@1+ (1,0) [0|15] ""  PRG,SMT,C_ECU,C_ECU_GW
 SG_ BIU656_0_0_CHECK_SUM : 0|8@1+ (1,0) [0|255] ""  PRG,SMT,C_ECU,C_ECU_GW

BO_ 1621 BIU655: 8 BIU
 SG_ BIU655_4_0_BUZZER_PATTERN : 32|8@1+ (1,0) [0|240] ""  C_ECU_GW
 SG_ BIU655_3_0_BUZZER_VOL_REQ : 24|3@1+ (1,0) [0|7] ""  C_ECU_GW
 SG_ BIU655_3_3_RDEF_RELAY_REQ : 27|1@1+ (1,0) [0|1] ""  C_ECU_GW
 SG_ BIU655_3_4_WIPER_DEICER_REQ : 28|1@1+ (1,0) [0|1] ""  C_ECU_GW
 SG_ BIU655_3_5_FT_WIPER_REQ : 29|2@1+ (1,0) [0|3] ""  C_ECU_GW
 SG_ BIU655_2_0_RR_WIPER_REQ : 16|1@1+ (1,0) [0|1] ""  C_ECU_GW
 SG_ BIU655_2_1_WASHER_REQ : 17|2@1+ (1,0) [0|3] ""  C_ECU_GW
 SG_ BIU655_2_3_HL_WASHER_REQ : 19|1@1+ (1,0) [0|1] ""  C_ECU_GW
 SG_ BIU655_2_4_FT_FOG_RELAY_REQ : 20|1@1+ (1,0) [0|1] ""  C_ECU_GW
 SG_ BIU655_2_5_HEADLAMP_HI_REQ : 21|2@1+ (1,0) [0|3] ""  C_ECU_GW
 SG_ BIU655_2_7_HEADLAMP_LO_REQ : 23|1@1+ (1,0) [0|1] ""  C_ECU_GW
 SG_ BIU655_1_0_MSG_COUNTER : 8|4@1+ (1,0) [0|15] ""  C_ECU_GW
 SG_ BIU655_0_0_CHECK_SUM : 0|8@1+ (1,0) [0|255] ""  C_ECU_GW

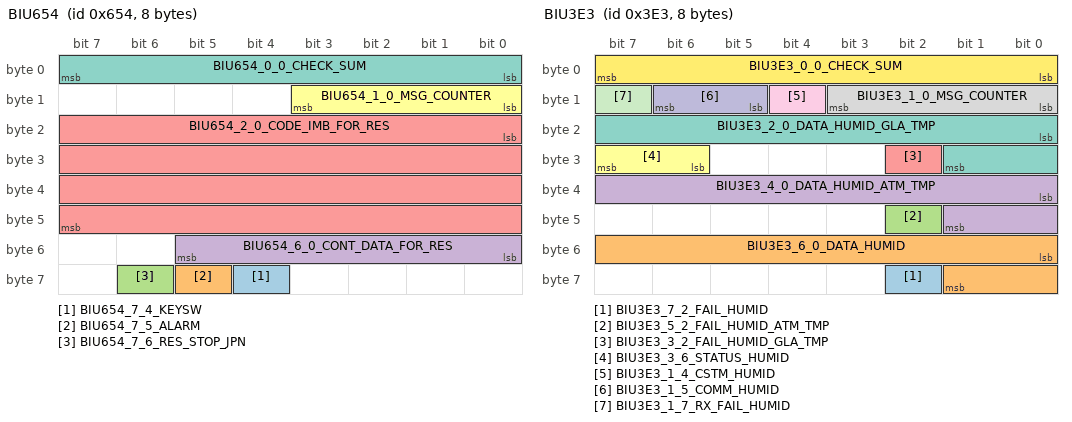
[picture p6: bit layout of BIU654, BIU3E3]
BO_ 1620 BIU654: 8 BIU
 SG_ BIU654_7_4_KEYSW : 60|1@1+ (1,0) [0|1] ""  C_ECU_GW
 SG_ BIU654_7_5_ALARM : 61|1@1+ (1,0) [0|1] ""  SMT,C_ECU,C_ECU_GW
 SG_ BIU654_7_6_RES_STOP_JPN : 62|1@1+ (1,0) [0|1] ""  C_ECU_GW
 SG_ BIU654_6_0_CONT_DATA_FOR_RES : 48|6@1+ (1,0) [0|63] ""  C_ECU_GW
 SG_ BIU654_2_0_CODE_IMB_FOR_RES : 16|32@1+ (1,0) [0|4294967295] ""  C_ECU_GW
 SG_ BIU654_1_0_MSG_COUNTER : 8|4@1+ (1,0) [0|15] ""  C_ECU,C_ECU_GW
 SG_ BIU654_0_0_CHECK_SUM : 0|8@1+ (1,0) [0|255] ""  C_ECU,C_ECU_GW

BO_ 1618 BIU652: 8 BIU
 SG_ BIU652_7_0_IND_SECURITY_IMB : 56|8@1+ (1,0) [0|240] ""  DKY,C_ECU_GW
 SG_ BIU652_6_0_OCCUPATION_3RDRH : 48|1@1+ (1,0) [0|1] ""  C_ECU_GW
 SG_ BIU652_6_1_OCCUPATION_3RDCTR : 49|1@1+ (1,0) [0|1] ""  C_ECU_GW
 SG_ BIU652_6_2_OCCUPATION_3RDLH : 50|1@1+ (1,0) [0|1] ""  C_ECU_GW
 SG_ BIU652_6_3_OCCUPATION_RRRH : 51|1@1+ (1,0) [0|1] ""  C_ECU,C_ECU_GW
 SG_ BIU652_6_4_OCCUPATION_RRCTR : 52|1@1+ (1,0) [0|1] ""  C_ECU,C_ECU_GW
 SG_ BIU652_6_5_OCCUPATION_RRLH : 53|1@1+ (1,0) [0|1] ""  C_ECU,C_ECU_GW
 SG_ BIU652_6_6_HORNHAZARD_RES_SIG : 54|1@1+ (1,0) [0|1] ""  C_ECU_GW
 SG_ BIU652_6_7_OCCUPATION_DRVR : 55|1@1+ (1,0) [0|1] ""  C_ECU,C_ECU_GW
 SG_ BIU652_5_0_STATUS_ROOMLAMP : 40|3@1+ (1,0) [0|7] ""  SMT,C_ECU_GW
 SG_ BIU652_5_3_HEADLAMP_SMALL : 43|1@1+ (1,0) [0|1] ""  SMT,C_ECU_GW
 SG_ BIU652_5_4_ALL_UNLOCK_STATE : 44|1@1+ (1,0) [0|1] ""  C_ECU_GW
 SG_ BIU652_5_5_DRVR_UNLOCK_STATE : 45|1@1+ (1,0) [0|1] ""  C_ECU_GW
 SG_ BIU652_5_6_ALL_LOCK_STATE : 46|1@1+ (1,0) [0|1] ""  C_ECU,C_ECU_GW
 SG_ BIU652_4_0_TRIG_LOCK_UNLOCK : 32|8@1+ (1,0) [0|255] ""  DKY,SMT,C_ECU,C_ECU_GW
 SG_ BIU652_3_0_DOOR_DRVR : 24|1@1+ (1,0) [0|1] ""  DKY,SMT,C_ECU_GW
 SG_ BIU652_3_1_DOOR_PASS : 25|1@1+ (1,0) [0|1] ""  DKY,SMT,C_ECU_GW
 SG_ BIU652_3_2_DOOR_RRRH : 26|1@1+ (1,0) [0|1] ""  DKY,SMT,C_ECU_GW
 SG_ BIU652_3_3_DOOR_RRLH : 27|1@1+ (1,0) [0|1] ""  DKY,SMT,C_ECU_GW
 SG_ BIU652_3_4_DOOR_RG : 28|1@1+ (1,0) [0|1] ""  DKY,SMT,C_ECU_GW
 SG_ BIU652_3_5_DOOR_TR : 29|1@1+ (1,0) [0|1] ""  DKY,SMT,C_ECU_GW
 SG_ BIU652_3_7_OPENSW_RG : 31|1@1+ (1,0) [0|1] ""  SMT,C_ECU,C_ECU_GW
 SG_ BIU652_2_0_LOCKSTATUS_DRVR : 16|1@1+ (1,0) [0|1] ""  DKY,SMT,C_ECU,C_ECU_GW
 SG_ BIU652_2_1_LOCKSTATUS_PASS : 17|1@1+ (1,0) [0|1] ""  DKY,SMT,C_ECU,C_ECU_GW
 SG_ BIU652_2_2_LOCKSTATUS_RRRH : 18|1@1+ (1,0) [0|1] ""  DKY,SMT,C_ECU,C_ECU_GW
 SG_ BIU652_2_3_LOCKSTATUS_RRLH : 19|1@1+ (1,0) [0|1] ""  DKY,SMT,C_ECU,C_ECU_GW
 SG_ BIU652_2_4_LOCKSTATUS_RG : 20|1@1+ (1,0) [0|1] ""  DKY,SMT,C_ECU,C_ECU_GW
 SG_ BIU652_2_6_UNLOCK_DOORKEYSW : 22|1@1+ (1,0) [0|1] ""  DKY,SMT,C_ECU_GW
 SG_ BIU652_2_7_LOCK_DOORKEYSW : 23|1@1+ (1,0) [0|1] ""  DKY,SMT,C_ECU_GW
 SG_ BIU652_1_0_MSG_COUNTER : 8|4@1+ (1,0) [0|15] ""  DKY,C_ECU,C_ECU_GW
 SG_ BIU652_0_0_CHECK_SUM : 0|8@1+ (1,0) [0|255] ""  DKY,C_ECU,C_ECU_GW

BO_ 1617 BIU651: 8 BIU
 SG_ BIU651_7_0_PWPOS_RL : 56|2@1+ (1,0) [0|3] ""  C_ECU,C_ECU_GW
 SG_ BIU651_7_2_PWPOS_RR : 58|2@1+ (1,0) [0|3] ""  C_ECU,C_ECU_GW
 SG_ BIU651_7_4_PWPOS_PASS : 60|2@1+ (1,0) [0|3] ""  C_ECU,C_ECU_GW
 SG_ BIU651_7_6_PWPOS_DRVR : 62|2@1+ (1,0) [0|3] ""  C_ECU,C_ECU_GW
 SG_ BIU651_6_0_IND_ACTIVE_HBA : 48|2@1+ (1,0) [0|3] ""  C_ECU_GW
 SG_ BIU651_6_2_ADB_ACTIVE : 50|1@1+ (1,0) [0|1] ""  C_ECU_GW
 SG_ BIU651_6_3_JUDGE_ILL : 51|1@1+ (1,0) [0|1] ""  AHL,C_ECU_GW
 SG_ BIU651_6_4_TYPE_LO_BEAM : 52|2@1+ (1,0) [0|3] ""  C_ECU_GW
 SG_ BIU651_6_6_TYPE_HI_BEAM : 54|2@1+ (1,0) [0|3] ""  C_ECU_GW
 SG_ BIU651_5_0_SRF_ACTIVE : 40|1@1+ (1,0) [0|1] ""  C_ECU_GW
 SG_ BIU651_5_1_SRF_IND : 41|2@1+ (1,0) [0|3] ""  C_ECU_GW
 SG_ BIU651_5_3_SRF_LAMP_LIGHT : 43|1@1+ (1,0) [0|1] ""  C_ECU_GW
 SG_ BIU651_5_4_SRF_LAMP_LEFT : 44|1@1+ (1,0) [0|1] ""  C_ECU_GW
 SG_ BIU651_5_5_MSG_STATUS_HBA : 45|2@1+ (1,0) [0|3] ""  C_ECU_GW
 SG_ BIU651_5_7_IND_FAIL_HBA : 47|1@1+ (1,0) [0|1] ""  C_ECU_GW
 SG_ BIU651_4_0_BUZ_PATTERN : 32|4@1+ (1,0) [0|8] ""  C_ECU_GW
 SG_ BIU651_4_4_CSTM_OPE_ALARM : 36|2@1+ (1,0) [0|3] ""  C_ECU_GW
 SG_ BIU651_4_6_CSTM_HBA : 38|2@1+ (1,0) [0|3] ""  C_ECU_GW
 SG_ BIU651_3_0_HEADLAMP_PASS_SW : 24|1@1+ (1,0) [0|1] ""  AHL,C_ECU_GW
 SG_ BIU651_3_1_HEADLAMP_AUTO_SW : 25|1@1+ (1,0) [0|1] ""  C_ECU_GW
 SG_ BIU651_3_2_JUDGE_DOOR_LOCK : 26|1@1+ (1,0) [0|1] ""  C_ECU_GW
 SG_ BIU651_3_3_JUDGE_DOOR_UNLOCK : 27|1@1+ (1,0) [0|1] ""  C_ECU_GW
 SG_ BIU651_3_4_HEADLAMP_Lo_SW : 28|1@1+ (1,0) [0|1] ""  AHL,C_ECU_GW
 SG_ BIU651_3_5_HEADLAMP_HI_SW : 29|1@1+ (1,0) [0|1] ""  AHL,C_ECU_GW
 SG_ BIU651_3_6_WIPER_AUTO_SW : 30|1@1+ (1,0) [0|1] ""  C_ECU_GW
 SG_ BIU651_3_7_PRG_LIN_MEMORY_ON_OFF : 31|1@1+ (1,0) [0|1] ""  C_ECU_GW
 SG_ BIU651_2_0_CSTM_ILLUMI_SSR : 16|1@1+ (1,0) [0|1] ""  C_ECU_GW
 SG_ BIU651_2_1_HANDLE : 17|1@1+ (1,0) [0|1] ""  C_ECU_GW
 SG_ BIU651_2_2_CSTM_SMT : 18|1@1+ (1,0) [0|1] ""  C_ECU_GW
 SG_ BIU651_2_3_AJARDOOR_STATUS : 19|1@1+ (1,0) [0|1] ""  C_ECU,C_ECU_GW
 SG_ BIU651_2_4_ONETOUCH_LAMP_OUT : 20|1@1+ (1,0) [0|1] ""  C_ECU_GW
 SG_ BIU651_2_5_PRG_FAIL_FLAG : 21|1@1+ (1,0) [0|1] ""  C_ECU_GW
 SG_ BIU651_2_6_CSTM_PSMECU : 22|1@1+ (1,0) [0|1] ""  C_ECU_GW
 SG_ BIU651_2_7_STATE_REGIST_DEL : 23|1@1+ (1,0) [0|1] ""  C_ECU_GW
 SG_ BIU651_1_0_MSG_COUNTER : 8|4@1+ (1,0) [0|15] ""  C_ECU,C_ECU_GW
 SG_ BIU651_1_4_SRPOS : 12|3@1+ (1,0) [0|7] ""  C_ECU,C_ECU_GW
 SG_ BIU651_1_7_WIPER_INT_STATUS : 15|1@1+ (1,0) [0|1] ""  C_ECU_GW
 SG_ BIU651_0_0_CHECK_SUM : 0|8@1+ (1,0) [0|255] ""  C_ECU,C_ECU_GW

BO_ 995 BIU3E3: 8 BIU
 SG_ BIU3E3_7_2_FAIL_HUMID : 58|1@1+ (1,0) [0|1] ""  ACN,C_ECU_GW
 SG_ BIU3E3_6_0_DATA_HUMID : 48|10@1+ (0.5,0) [0|100] "%"  ACN,C_ECU_GW
 SG_ BIU3E3_5_2_FAIL_HUMID_ATM_TMP : 42|1@1+ (1,0) [0|1] ""  ACN,C_ECU_GW
 SG_ BIU3E3_4_0_DATA_HUMID_ATM_TMP : 32|10@1+ (0.1,-40) [-40|62.3] "degC"  ACN,C_ECU_GW
 SG_ BIU3E3_3_2_FAIL_HUMID_GLA_TMP : 26|1@1+ (1,0) [0|1] ""  ACN,C_ECU_GW
 SG_ BIU3E3_3_6_STATUS_HUMID : 30|2@1+ (1,0) [0|3] ""  ACN,C_ECU_GW
 SG_ BIU3E3_2_0_DATA_HUMID_GLA_TMP : 16|10@1+ (0.1,-40) [-40|62.3] "degC"  ACN,C_ECU_GW
 SG_ BIU3E3_1_0_MSG_COUNTER : 8|4@1+ (1,0) [0|15] ""  ACN,C_ECU_GW
 SG_ BIU3E3_1_4_CSTM_HUMID : 12|1@1+ (1,0) [0|1] ""  ACN,C_ECU_GW
 SG_ BIU3E3_1_5_COMM_HUMID : 13|2@1+ (1,0) [0|3] ""  ACN,C_ECU_GW
 SG_ BIU3E3_1_7_RX_FAIL_HUMID : 15|1@1+ (1,0) [0|1] ""  ACN,C_ECU_GW
 SG_ BIU3E3_0_0_CHECK_SUM : 0|8@1+ (1,0) [0|255] ""  ACN,C_ECU_GW

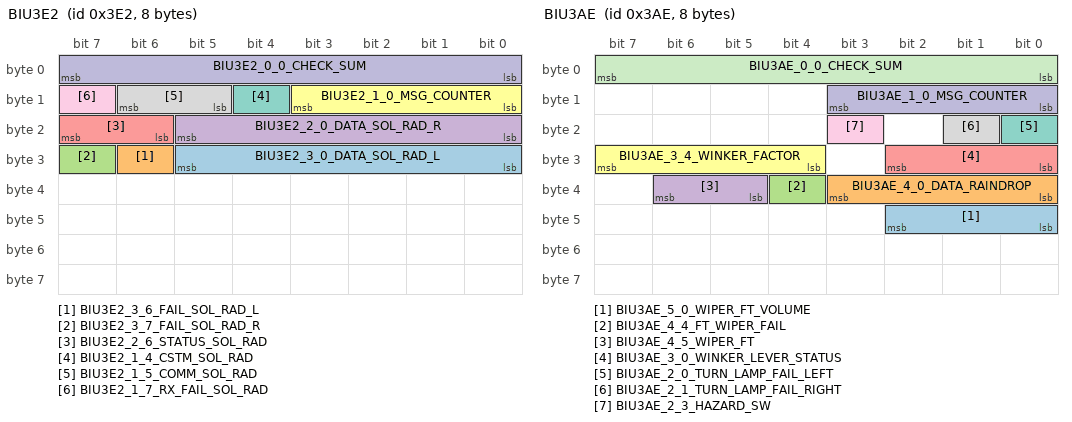
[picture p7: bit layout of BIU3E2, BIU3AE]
BO_ 994 BIU3E2: 8 BIU
 SG_ BIU3E2_3_0_DATA_SOL_RAD_L : 24|6@1+ (20,0) [0|1260] "W/m2"  ACN
 SG_ BIU3E2_3_6_FAIL_SOL_RAD_L : 30|1@1+ (1,0) [0|1] ""  ACN
 SG_ BIU3E2_3_7_FAIL_SOL_RAD_R : 31|1@1+ (1,0) [0|1] ""  ACN
 SG_ BIU3E2_2_0_DATA_SOL_RAD_R : 16|6@1+ (20,0) [0|1260] "W/m2"  ACN
 SG_ BIU3E2_2_6_STATUS_SOL_RAD : 22|2@1+ (1,0) [0|3] ""  ACN
 SG_ BIU3E2_1_0_MSG_COUNTER : 8|4@1+ (1,0) [0|15] ""  ACN
 SG_ BIU3E2_1_4_CSTM_SOL_RAD : 12|1@1+ (1,0) [0|1] ""  ACN
 SG_ BIU3E2_1_5_COMM_SOL_RAD : 13|2@1+ (1,0) [0|3] ""  ACN
 SG_ BIU3E2_1_7_RX_FAIL_SOL_RAD : 15|1@1+ (1,0) [0|1] ""  ACN
 SG_ BIU3E2_0_0_CHECK_SUM : 0|8@1+ (1,0) [0|255] ""  ACN

BO_ 942 BIU3AE: 8 BIU
 SG_ BIU3AE_5_0_WIPER_FT_VOLUME : 40|3@1+ (1,0) [0|5] ""  C_ECU_GW
 SG_ BIU3AE_4_0_DATA_RAINDROP : 32|4@1+ (1,0) [0|8] ""  C_ECU_GW
 SG_ BIU3AE_4_4_FT_WIPER_FAIL : 36|1@1+ (1,0) [0|1] ""  C_ECU_GW
 SG_ BIU3AE_4_5_WIPER_FT : 37|2@1+ (1,0) [0|3] ""  C_ECU_GW
 SG_ BIU3AE_3_0_WINKER_LEVER_STATUS : 24|3@1+ (1,0) [0|5] ""  C_ECU_GW
 SG_ BIU3AE_3_4_WINKER_FACTOR : 28|4@1+ (1,0) [0|15] ""  C_ECU,C_ECU_GW
 SG_ BIU3AE_2_0_TURN_LAMP_FAIL_LEFT : 16|1@1+ (1,0) [0|1] ""  C_ECU_GW
 SG_ BIU3AE_2_1_TURN_LAMP_FAIL_RIGHT : 17|1@1+ (1,0) [0|1] ""  C_ECU_GW
 SG_ BIU3AE_2_3_HAZARD_SW : 19|1@1+ (1,0) [0|1] ""  C_ECU,C_ECU_GW
 SG_ BIU3AE_1_0_MSG_COUNTER : 8|4@1+ (1,0) [0|15] ""  C_ECU_GW
 SG_ BIU3AE_0_0_CHECK_SUM : 0|8@1+ (1,0) [0|255] ""  C_ECU_GW

BO_ 940 BIU3AC: 8 BIU
 SG_ BIU3AC_7_0_HEADLAMP_SMALL : 56|1@1+ (1,0) [0|1] ""  EAM_HUD,C_ECU_GW
 SG_ BIU3AC_7_1_HEADLAMP_LO_REQ : 57|1@1+ (1,0) [0|1] ""  AHL,C_ECU_GW
 SG_ BIU3AC_7_2_HEADLAMP_HI_REQ : 58|1@1+ (1,0) [0|1] ""  AHL,C_ECU,C_ECU_GW
 SG_ BIU3AC_7_3_FT_FOG_RELAY_REQ : 59|1@1+ (1,0) [0|1] ""  C_ECU,C_ECU_GW
 SG_ BIU3AC_7_4_FOGLAMP_RR : 60|1@1+ (1,0) [0|1] ""  C_ECU_GW
 SG_ BIU3AC_7_5_DRL : 61|1@1+ (1,0) [0|1] ""  C_ECU_GW
 SG_ BIU3AC_7_6_WIPER_FRONT : 62|1@1+ (1,0) [0|1] ""  C_ECU,C_ECU_GW
 SG_ BIU3AC_7_7_RDEF_RELAY_REQ : 63|1@1+ (1,0) [0|1] ""  MCR,MCL,C_ECU_GW
 SG_ BIU3AC_6_0_RDEFOGSW : 48|1@1+ (1,0) [0|1] ""  ACN,C_ECU_GW
 SG_ BIU3AC_6_1_CSTM_PRG : 49|1@1+ (1,0) [0|1] ""  C_ECU_GW
 SG_ BIU3AC_6_2_FAIL_SHIFTLOCKSOL : 50|1@1+ (1,0) [0|1] ""  C_ECU_GW
 SG_ BIU3AC_6_3_REQ_CANCEL_ISS : 51|1@1+ (1,0) [0|1] ""  C_ECU_GW
 SG_ BIU3AC_6_4_REVERSE_MT : 52|1@1+ (1,0) [0|1] ""  SRM,AHL,TPM,C_ECU_GW
 SG_ BIU3AC_6_5_HANDBRAKE : 53|1@1+ (1,0) [0|1] ""  C_ECU_GW
 SG_ BIU3AC_6_6_BRAKELAMPSW : 54|1@1+ (1,0) [0|1] ""  AHL,SMT,C_ECU,C_ECU_GW
 SG_ BIU3AC_6_7_TOWING_SW : 55|1@1+ (1,0) [0|1] ""  C_ECU_GW
 SG_ BIU3AC_5_0_LANE_OFF_SW : 40|2@1+ (1,0) [0|3] ""  C_ECU_GW
 SG_ BIU3AC_5_2_PCR_OFF_SW : 42|2@1+ (1,0) [0|3] ""  C_ECU_GW
 SG_ BIU3AC_5_4_DIMMER_CANCEL : 44|1@1+ (1,0) [0|1] ""  C_ECU_GW
 SG_ BIU3AC_5_5_KEYSW : 45|1@1+ (1,0) [0|1] ""  C_ECU_GW
 SG_ BIU3AC_5_6_IND_ND_SHIFTLOCK : 46|1@1+ (1,0) [0|1] ""  C_ECU_GW
 SG_ BIU3AC_4_0_DOOR_DRVR : 32|1@1+ (1,0) [0|1] ""  DKY,ACN,C_ECU,C_ECU_GW
 SG_ BIU3AC_4_1_DOOR_PASS : 33|1@1+ (1,0) [0|1] ""  DKY,ACN,C_ECU,C_ECU_GW
 SG_ BIU3AC_4_2_DOOR_RRRH : 34|1@1+ (1,0) [0|1] ""  DKY,ACN,C_ECU,C_ECU_GW
 SG_ BIU3AC_4_3_DOOR_RRLH : 35|1@1+ (1,0) [0|1] ""  DKY,ACN,C_ECU,C_ECU_GW
 SG_ BIU3AC_4_4_DOOR_RG : 36|1@1+ (1,0) [0|1] ""  DKY,ACN,C_ECU,C_ECU_GW
 SG_ BIU3AC_4_5_DOOR_TR : 37|1@1+ (1,0) [0|1] ""  ACN,C_ECU,C_ECU_GW
 SG_ BIU3AC_4_6_HOOD_CLOSE : 38|1@1+ (1,0) [0|1] ""  SMT,C_ECU_GW
 SG_ BIU3AC_4_7_HOOD_OPEN : 39|1@1+ (1,0) [0|1] ""  C_ECU_GW
 SG_ BIU3AC_3_0_GW_STSW_RES : 24|1@1+ (1,0) [0|1] ""  C_ECU_GW
 SG_ BIU3AC_3_1_GW_POWER_RES : 25|2@1+ (1,0) [0|2] ""  C_ECU_GW
 SG_ BIU3AC_3_3_ST1 : 27|1@1+ (1,0) [0|1] ""  C_ECU_GW
 SG_ BIU3AC_3_4_ST2 : 28|1@1+ (1,0) [0|1] ""  C_ECU_GW
 SG_ BIU3AC_3_5_ACC : 29|1@1+ (1,0) [0|1] ""  SMT,C_ECU_GW
 SG_ BIU3AC_3_6_IGA : 30|1@1+ (1,0) [0|1] ""  SMT,TPM,C_ECU_GW
 SG_ BIU3AC_3_7_BAT_BACKUP : 31|1@1+ (1,0) [0|1] ""  SMT,ACN,C_ECU,C_ECU_GW
 SG_ BIU3AC_2_0_CSTM_AC : 16|1@1+ (1,0) [0|1] ""  C_ECU_GW
 SG_ BIU3AC_2_1_IMB_SMT : 17|2@1+ (1,0) [0|3] ""  C_ECU_GW
 SG_ BIU3AC_2_3_CSTM_WGN_SDN : 19|1@1+ (1,0) [0|1] ""  DKY,SMT,C_ECU_GW
 SG_ BIU3AC_2_4_VAL_SEAT_BACK_CTSM : 20|1@1+ (1,0) [0|1] ""  C_ECU_GW
 SG_ BIU3AC_2_5_VAL_MIR_AFOLD_CTSM : 21|1@1+ (1,0) [0|1] ""  C_ECU_GW
 SG_ BIU3AC_2_6_VAL_MIR_RTILT_CTSM : 22|1@1+ (1,0) [0|1] ""  C_ECU_GW
 SG_ BIU3AC_2_7_WIPER_REAR : 23|1@1+ (1,0) [0|1] ""  C_ECU_GW
 SG_ BIU3AC_1_0_MSG_COUNTER : 8|4@1+ (1,0) [0|15] ""  DKY,MCR,MCL,AHL,SMT,ACN,C_ECU,C_ECU_GW
 SG_ BIU3AC_1_4_PADDLESHIFT_DOWN_SW : 12|1@1+ (1,0) [0|1] ""  C_ECU_GW
 SG_ BIU3AC_1_5_PADDLESHIFT_UP_SW : 13|1@1+ (1,0) [0|1] ""  C_ECU_GW
 SG_ BIU3AC_1_6_MANUALMODE_SW : 14|1@1+ (1,0) [0|1] ""  C_ECU_GW
 SG_ BIU3AC_0_0_CHECK_SUM : 0|8@1+ (1,0) [0|255] ""  DKY,MCR,MCL,ACN,C_ECU,C_ECU_GW

BO_ 1286 BIU506: 8 BIU
 SG_ BIU506_1_4_ActiveWakeUpBit : 12|1@1+ (1,0) [0|1] ""  PSC,MCR,MCL,PRG,SMT,TPM,C_ECU
 SG_ BIU506_0_0_SourceNodeID : 0|8@1+ (1,0) [0|255] ""  PSC,MCR,MCL,PRG,SMT,TPM,C_ECU

BO_ 960 BIU3C0: 8 BIU

BO_ 1616 BIU650: 8 BIU
 SG_ BIU650_7_0_Reserved : 56|1@1+ (1,0) [0|1] ""  C_ECU_GW
 SG_ BIU650_7_1_Reserved : 57|1@1+ (1,0) [0|1] ""  C_ECU_GW
 SG_ BIU650_7_2_Reserved : 58|1@1+ (1,0) [0|1] ""  C_ECU_GW
 SG_ BIU650_7_3_DOOR_LINK_SW_STS : 59|1@1+ (1,0) [0|1] ""  C_ECU_GW
 SG_ BIU650_7_4_Reserved : 60|1@1+ (1,0) [0|1] ""  C_ECU_GW
 SG_ BIU650_6_0_Reserved : 48|3@1+ (1,0) [0|7] ""  C_ECU_GW
 SG_ BIU650_6_3_RR_WIPER_STATUS : 51|2@1+ (1,0) [0|3] ""  C_ECU_GW
 SG_ BIU650_6_5_WIPER_SENSITIVITY_CTM : 53|2@1+ (1,0) [0|3] ""  C_ECU_GW
 SG_ BIU650_5_0_Reserved : 40|1@1+ (1,0) [0|1] ""  C_ECU_GW
 SG_ BIU650_5_1_Reserved : 41|1@1+ (1,0) [0|1] ""  C_ECU_GW
 SG_ BIU650_5_2_FMH_DOOR_LOCK : 42|2@1+ (1,0) [0|3] ""  C_ECU,C_ECU_GW
 SG_ BIU650_5_4_LMH_DOOR_LOCK : 44|2@1+ (1,0) [0|3] ""  C_ECU,C_ECU_GW
 SG_ BIU650_4_0_REQ_OPE_AUTOLIGHT : 32|2@1+ (1,0) [0|3] ""  C_ECU,C_ECU_GW
 SG_ BIU650_4_2_STATE_SHINSSR : 34|2@1+ (1,0) [0|3] ""  C_ECU,C_ECU_GW
 SG_ BIU650_4_4_STATE_RLS_FAIL : 36|2@1+ (1,0) [0|3] ""  C_ECU,C_ECU_GW
 SG_ BIU650_3_0_REQ_FWASHER_ITLOCK : 24|1@1+ (1,0) [0|1] ""  C_ECU,C_ECU_GW
 SG_ BIU650_3_1_FWIPER_RTN : 25|1@1+ (1,0) [0|1] ""  C_ECU,C_ECU_GW
 SG_ BIU650_3_2_TURN_LAMP_STATE_LEFT : 26|1@1+ (1,0) [0|1] ""  C_ECU,C_ECU_GW
 SG_ BIU650_3_3_TURN_LAMP_STATE_RIGHT : 27|1@1+ (1,0) [0|1] ""  C_ECU,C_ECU_GW
 SG_ BIU650_3_4_Reserved : 28|1@1+ (1,0) [0|1] ""  C_ECU_GW
 SG_ BIU650_2_0_HEADLAMP_SMALL_SW : 16|1@1+ (1,0) [0|1] ""  C_ECU,C_ECU_GW
 SG_ BIU650_2_1_HEADLAMP_LO_SW : 17|1@1+ (1,0) [0|1] ""  C_ECU,C_ECU_GW
 SG_ BIU650_2_2_HEADLAMP_OFF_SW : 18|1@1+ (1,0) [0|1] ""  C_ECU,C_ECU_GW
 SG_ BIU650_2_3_HEADLAMP_Hi_SW : 19|1@1+ (1,0) [0|1] ""  C_ECU,C_ECU_GW
 SG_ BIU650_2_4_HEAD_LAMP_PASS_SW : 20|1@1+ (1,0) [0|1] ""  C_ECU,C_ECU_GW
 SG_ BIU650_2_5_FFOG_SW : 21|1@1+ (1,0) [0|1] ""  C_ECU,C_ECU_GW
 SG_ BIU650_2_6_RFOG_SW : 22|1@1+ (1,0) [0|1] ""  C_ECU,C_ECU_GW
 SG_ BIU650_1_0_MSG_COUNTER : 8|4@1+ (1,0) [0|15] ""  C_ECU,C_ECU_GW
 SG_ BIU650_0_0_CHECK_SUM : 0|8@1+ (1,0) [0|255] ""  C_ECU,C_ECU_GW

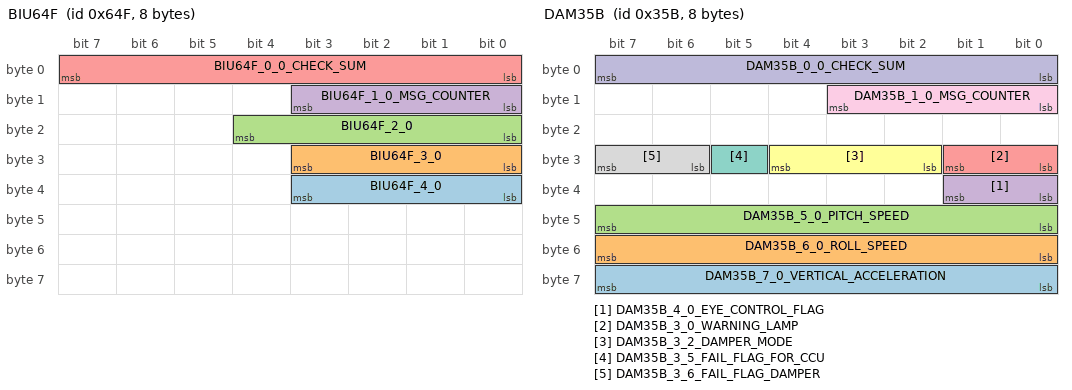
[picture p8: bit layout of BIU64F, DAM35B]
BO_ 1615 BIU64F: 8 BIU
 SG_ BIU64F_4_0 : 32|4@1+ (1,0) [0|15] ""  C_ECU_GW
 SG_ BIU64F_3_0 : 24|4@1+ (1,0) [0|15] ""  C_ECU_GW
 SG_ BIU64F_2_0 : 16|5@1+ (1,0) [0|31] ""  C_ECU_GW
 SG_ BIU64F_1_0_MSG_COUNTER : 8|4@1+ (1,0) [0|15] ""  C_ECU_GW
 SG_ BIU64F_0_0_CHECK_SUM : 0|8@1+ (1,0) [0|255] ""  C_ECU_GW

BO_ 859 DAM35B: 8 DAM
 SG_ DAM35B_7_0_VERTICAL_ACCELERATION : 56|8@1- (0.05,0) [-6.4|6.35] "m/s2"  C_ECU_GW
 SG_ DAM35B_6_0_ROLL_SPEED : 48|8@1- (0.15,0) [-19.2|19.05] "deg/s"  C_ECU_GW
 SG_ DAM35B_5_0_PITCH_SPEED : 40|8@1- (0.3,0) [-38.4|38.1] "deg/s"  C_ECU_GW
 SG_ DAM35B_4_0_EYE_CONTROL_FLAG : 32|2@1+ (1,0) [0|3] ""  C_ECU_GW
 SG_ DAM35B_3_0_WARNING_LAMP : 24|2@1+ (1,0) [0|3] ""  C_ECU_GW
 SG_ DAM35B_3_2_DAMPER_MODE : 26|3@1+ (1,0) [0|7] ""  C_ECU_GW
 SG_ DAM35B_3_5_FAIL_FLAG_FOR_CCU : 29|1@1+ (1,0) [0|1] ""  C_ECU_GW
 SG_ DAM35B_3_6_FAIL_FLAG_DAMPER : 30|2@1+ (1,0) [0|3] ""  C_ECU_GW
 SG_ DAM35B_1_0_MSG_COUNTER : 8|4@1+ (1,0) [0|15] ""  C_ECU_GW
 SG_ DAM35B_0_0_CHECK_SUM : 0|8@1+ (1,0) [0|255] ""  C_ECU_GW

BO_ 1368 DAM558: 8 DAM
 SG_ DAM558_0_0_NETWORK_STATUS : 0|64@1+ (1,0) [0|0] ""  C_ECU

BO_ 811 EPB32B: 8 C_ECU_GW
 SG_ EPB32B_7_0_AVH_TARGET_PRESS : 56|8@1+ (0.0235,0) [0|255] "MPa" Vector__XXX
 SG_ EPB32B_6_0_VEHICLE_RUN_STOP_FLG : 48|2@1+ (1,0) [0|3] "" Vector__XXX
 SG_ EPB32B_6_2_REQ_HILL_P_CAUTION : 50|1@1+ (1,0) [0|1] "" Vector__XXX
 SG_ EPB32B_5_0_FLG_AVH_OILPRES_EPB : 40|1@1+ (1,0) [0|1] "" Vector__XXX
 SG_ EPB32B_5_1_FLG_AVH : 41|1@1+ (1,0) [0|1] "" Vector__XXX
 SG_ EPB32B_5_2_AVH_INTENSIFY_PRES : 42|1@1+ (1,0) [0|1] "" Vector__XXX
 SG_ EPB32B_5_3_BREAK_IND : 43|2@1+ (1,0) [0|3] "" Vector__XXX
 SG_ EPB32B_5_5_AVH_ON_LAMP : 45|1@1+ (1,0) [0|1] "" Vector__XXX
 SG_ EPB32B_5_6_AVH_FUNC_ON_LUMP : 46|1@1+ (1,0) [0|1] "" Vector__XXX
 SG_ EPB32B_5_7_AVH_ACTIVE : 47|1@1+ (1,0) [0|1] "" Vector__XXX
 SG_ EPB32B_4_0_BUZZER : 32|2@1+ (1,0) [0|3] "" Vector__XXX
 SG_ EPB32B_4_2_HILL_HOLD_ON_LAMP : 34|1@1+ (1,0) [0|1] "" Vector__XXX
 SG_ EPB32B_4_3_CLAMP_LAMP : 35|2@1+ (1,0) [0|3] "" Vector__XXX
 SG_ EPB32B_4_5_WARN_LAMP : 37|2@1+ (1,0) [0|3] "" Vector__XXX
 SG_ EPB32B_4_7_WARN_EPB_MET_LCD : 39|1@1+ (1,0) [0|1] "" Vector__XXX
 SG_ EPB32B_3_0_STATUS_EPB : 24|3@1+ (1,0) [0|7] ""  BIU
 SG_ EPB32B_3_3_DYNAMIC_PARKING : 27|1@1+ (1,0) [0|1] "" Vector__XXX
 SG_ EPB32B_3_4_HILL_HOLD_RUN_FLG : 28|1@1+ (1,0) [0|1] ""  BIU
 SG_ EPB32B_3_5_INHIBIT_ISS_DELAY : 29|1@1+ (1,0) [0|1] "" Vector__XXX
 SG_ EPB32B_3_6_INHIBIT_ISS : 30|1@1+ (1,0) [0|1] "" Vector__XXX
 SG_ EPB32B_3_7_AVH_PERMIT_CONT_ACC : 31|1@1+ (1,0) [0|1] "" Vector__XXX
 SG_ EPB32B_2_0_ERR_INFO : 16|2@1+ (1,0) [0|3] "" Vector__XXX
 SG_ EPB32B_2_2_EPB_FAIL_FLG1 : 18|1@1+ (1,0) [0|1] "" Vector__XXX
 SG_ EPB32B_2_3_EPB_FAIL_FLG2 : 19|1@1+ (1,0) [0|1] "" Vector__XXX
 SG_ EPB32B_2_4_EPB_FAIL_FLG3 : 20|1@1+ (1,0) [0|1] "" Vector__XXX
 SG_ EPB32B_1_0_MSG_COUNTER : 8|4@1+ (1,0) [0|15] ""  BIU
 SG_ EPB32B_1_4_WAKE_UP_FRAME : 12|1@1+ (1,0) [0|1] "" Vector__XXX
 SG_ EPB32B_1_5_REQ_COMM_CONT : 13|1@1+ (1,0) [0|1] "" Vector__XXX
 SG_ EPB32B_1_6 : 14|1@1+ (1,0) [0|1] "" Vector__XXX
 SG_ EPB32B_0_0_CHECK_SUM : 0|8@1+ (1,0) [0|255] ""  BIU

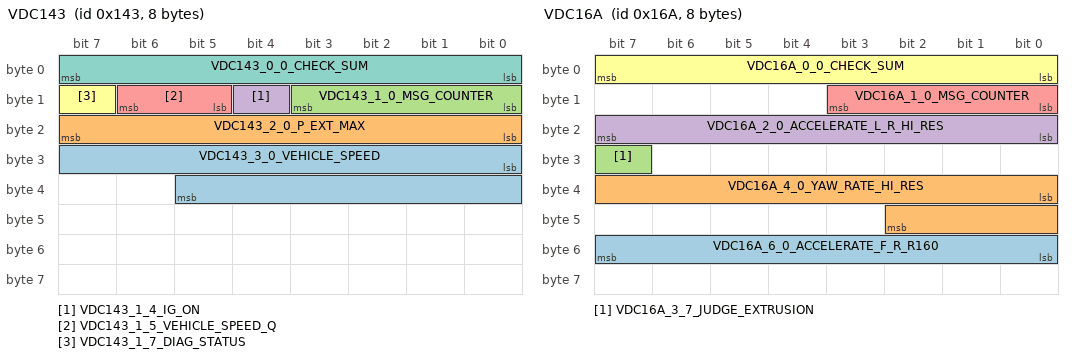
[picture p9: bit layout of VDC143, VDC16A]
BO_ 323 VDC143: 8 C_ECU_GW
 SG_ VDC143_3_0_VEHICLE_SPEED : 24|14@1+ (0.05625,0) [0|299.98125] "km/h"  SMT
 SG_ VDC143_2_0_P_EXT_MAX : 16|8@1+ (1,0) [0|250] "bar" Vector__XXX
 SG_ VDC143_1_0_MSG_COUNTER : 8|4@1+ (1,0) [0|15] ""  SMT
 SG_ VDC143_1_4_IG_ON : 12|1@1+ (1,0) [0|1] "" Vector__XXX
 SG_ VDC143_1_5_VEHICLE_SPEED_Q : 13|2@1+ (1,0) [0|3] "" Vector__XXX
 SG_ VDC143_1_7_DIAG_STATUS : 15|1@1+ (1,0) [0|1] "" Vector__XXX
 SG_ VDC143_0_0_CHECK_SUM : 0|8@1+ (1,0) [0|255] ""  SMT

BO_ 362 VDC16A: 8 C_ECU_GW
 SG_ VDC16A_6_0_ACCELERATE_F_R_R160 : 48|8@1- (0.2,0) [-17.6|17.6] "m/s^2" Vector__XXX
 SG_ VDC16A_4_0_YAW_RATE_HI_RES : 32|11@1- (0.1,0) [-85|85] "deg/s" Vector__XXX
 SG_ VDC16A_3_7_JUDGE_EXTRUSION : 31|1@1+ (1,0) [0|1] "" Vector__XXX
 SG_ VDC16A_2_0_ACCELERATE_L_R_HI_RES : 16|8@1- (0.1,0) [-7|7] "m/s2" Vector__XXX
 SG_ VDC16A_1_0_MSG_COUNTER : 8|4@1+ (1,0) [0|15] "" Vector__XXX
 SG_ VDC16A_0_0_CHECK_SUM : 0|8@1+ (1,0) [0|255] "" Vector__XXX

BO_ 316 VDC13C: 8 C_ECU_GW
 SG_ VDC13C_7_0_RCV_FAIL_ADA : 56|1@1+ (1,0) [0|1] "" Vector__XXX
 SG_ VDC13C_7_1_FAIL_PCU : 57|1@1+ (1,0) [0|1] "" Vector__XXX
 SG_ VDC13C_7_2_CONT_STATE_ES_BRAKE : 58|1@1+ (1,0) [0|1] "" Vector__XXX
 SG_ VDC13C_7_3_ASST_PRECRUSH_ACC : 59|1@1+ (1,0) [0|1] "" Vector__XXX
 SG_ VDC13C_7_4_CONT_STATE_PRECRUSH : 60|1@1+ (1,0) [0|1] "" Vector__XXX
 SG_ VDC13C_7_5_PERMIT_BRAKE_ACC : 61|1@1+ (1,0) [0|1] "" Vector__XXX
 SG_ VDC13C_7_6_DETECT_BRAKING : 62|1@1+ (1,0) [0|1] "" Vector__XXX
 SG_ VDC13C_7_7_EMERGENCY_BRAKE : 63|1@1+ (1,0) [0|1] ""  BIU
 SG_ VDC13C_6_0_SPD_PULSE_INTEGRAL : 48|6@1+ (1,0) [0|63] "" Vector__XXX
 SG_ VDC13C_6_6_VDC_OFF : 54|1@1+ (1,0) [0|1] "" Vector__XXX
 SG_ VDC13C_6_7_STBY_PREVIEW_VDC : 55|1@1+ (1,0) [0|1] "" Vector__XXX
 SG_ VDC13C_5_0_SPD_PULSE_RRRH : 40|7@1+ (1,0) [0|95] ""  TPM
 SG_ VDC13C_5_7_ACTIVATE_TSM : 47|1@1+ (1,0) [0|1] "" Vector__XXX
 SG_ VDC13C_4_0_SPD_PULSE_RRLH : 32|7@1+ (1,0) [0|95] ""  TPM
 SG_ VDC13C_4_7_ACTIVATE_RMI : 39|1@1+ (1,0) [0|1] "" Vector__XXX
 SG_ VDC13C_3_0_SPD_PULSE_FTRH : 24|7@1+ (1,0) [0|95] ""  TPM
 SG_ VDC13C_3_7_ACTIVATE_VECTARING : 31|1@1+ (1,0) [0|1] "" Vector__XXX
 SG_ VDC13C_2_0_SPD_PULSE_FTLH : 16|7@1+ (1,0) [0|95] ""  TPM
 SG_ VDC13C_2_7_STATE_ACTIVATE_HSA : 23|1@1+ (1,0) [0|1] "" Vector__XXX
 SG_ VDC13C_1_0_MSG_COUNTER : 8|4@1+ (1,0) [0|15] ""  BIU
 SG_ VDC13C_1_4_ACTIVE_BRAKEHOLD : 12|1@1+ (1,0) [0|1] "" Vector__XXX
 SG_ VDC13C_1_5_PROHIBIT_BRAKEHOLD : 13|1@1+ (1,0) [0|1] "" Vector__XXX
 SG_ VDC13C_1_6_BRAKELAMP_RELAY : 14|1@1+ (1,0) [0|1] "" Vector__XXX
 SG_ VDC13C_1_7_STATUS_BRAKELAMP : 15|1@1+ (1,0) [0|1] "" Vector__XXX
 SG_ VDC13C_0_0_CHECK_SUM : 0|8@1+ (1,0) [0|255] ""  BIU

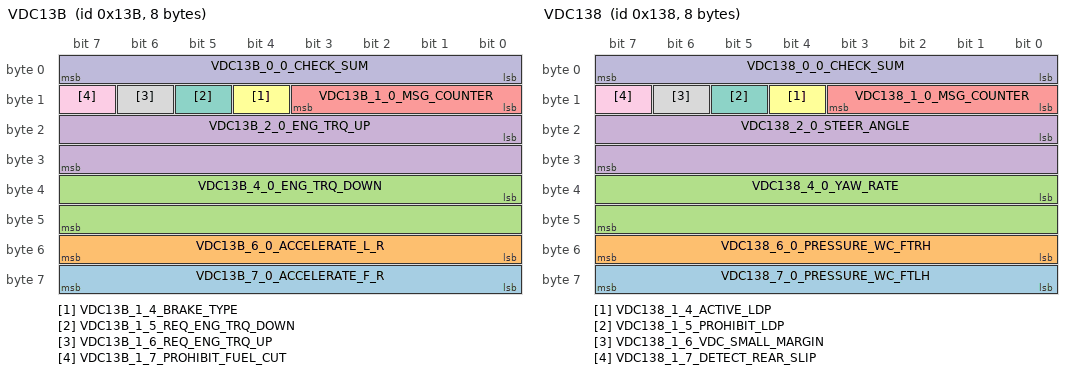
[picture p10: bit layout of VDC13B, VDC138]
BO_ 315 VDC13B: 8 C_ECU_GW
 SG_ VDC13B_7_0_ACCELERATE_F_R : 56|8@1- (0.1,0) [-12.5|12.5] "m/s^2"  DAM,BIU
 SG_ VDC13B_6_0_ACCELERATE_L_R : 48|8@1- (0.1923,0) [-17.64|17.64] "m/s^2"  DAM
 SG_ VDC13B_4_0_ENG_TRQ_DOWN : 32|16@1+ (0.1,-1000) [-1000|5553.5] "Nm" Vector__XXX
 SG_ VDC13B_2_0_ENG_TRQ_UP : 16|16@1+ (0.1,-1000) [-1000|5553.5] "Nm" Vector__XXX
 SG_ VDC13B_1_0_MSG_COUNTER : 8|4@1+ (1,0) [0|15] ""  DAM,BIU
 SG_ VDC13B_1_4_BRAKE_TYPE : 12|1@1+ (1,0) [0|1] "" Vector__XXX
 SG_ VDC13B_1_5_REQ_ENG_TRQ_DOWN : 13|1@1+ (1,0) [0|1] "" Vector__XXX
 SG_ VDC13B_1_6_REQ_ENG_TRQ_UP : 14|1@1+ (1,0) [0|1] "" Vector__XXX
 SG_ VDC13B_1_7_PROHIBIT_FUEL_CUT : 15|1@1+ (1,0) [0|1] "" Vector__XXX
 SG_ VDC13B_0_0_CHECK_SUM : 0|8@1+ (1,0) [0|255] ""  DAM,BIU

BO_ 313 VDC139: 8 C_ECU_GW
 SG_ VDC139_7_4_FAIL_PRESSURE_SSR : 60|1@1+ (1,0) [0|1] ""  AHL
 SG_ VDC139_7_5_STATUS_EPB : 61|3@1+ (1,0) [0|7] "" Vector__XXX
 SG_ VDC139_6_0_SSR_N_PRESS : 48|12@1+ (1,0) [193|3896] "" Vector__XXX
 SG_ VDC139_5_0_PRESSURE_BRAKE : 40|8@1+ (0.13058823529412,0) [0|25] "MPa"  AHL,DAM
 SG_ VDC139_4_0_HDC_STATUS : 32|2@1+ (1,0) [0|3] "" Vector__XXX
 SG_ VDC139_4_2_BRAKELAMPSW : 34|1@1+ (1,0) [0|1] ""  DAM
 SG_ VDC139_4_3_FAIL_BRAKELAMPSW : 35|1@1+ (1,0) [0|1] ""  DAM
 SG_ VDC139_4_4_ACTIVATE_ABS : 36|1@1+ (1,0) [0|1] ""  BIU
 SG_ VDC139_4_5_ACTIVATE_TCS : 37|1@1+ (1,0) [0|1] "" Vector__XXX
 SG_ VDC139_4_6_CONT_OVER_STR : 38|1@1+ (1,0) [0|1] "" Vector__XXX
 SG_ VDC139_4_7_CONT_UNDER_STR : 39|1@1+ (1,0) [0|1] "" Vector__XXX
 SG_ VDC139_3_5_FAIL_VDC_SSR : 29|1@1+ (1,0) [0|1] ""  DAM
 SG_ VDC139_3_6_FAIL_SPD_SSR_FHI : 30|1@1+ (1,0) [0|1] ""  DAM
 SG_ VDC139_3_7_FAIL_ABS_SYS : 31|1@1+ (1,0) [0|1] "" Vector__XXX
 SG_ VDC139_2_0_SPD_WHEEL_AVE : 16|13@1+ (0.05625,0) [0|299.98125] "km/h"  DKY,PSC,PRG,SRM,AHL,SMT,TPM,ACN,DAM,BIU
 SG_ VDC139_1_0_MSG_COUNTER : 8|4@1+ (1,0) [0|15] ""  PSC,PRG,SMT,ACN,DAM,BIU
 SG_ VDC139_1_4_FAIL_HDC_SYS : 12|1@1+ (1,0) [0|1] "" Vector__XXX
 SG_ VDC139_1_5_VEHICLE_HIGHT : 13|2@1+ (1,0) [0|2] "" Vector__XXX
 SG_ VDC139_1_7_REPROGRAMING : 15|1@1+ (1,0) [0|1] ""  EAM_HUD
 SG_ VDC139_0_0_CHECK_SUM : 0|8@1+ (1,0) [0|255] ""  PSC,PRG,SMT,ACN,DAM,BIU

BO_ 312 VDC138: 8 C_ECU_GW
 SG_ VDC138_7_0_PRESSURE_WC_FTLH : 56|8@1+ (0.08,0) [0|20.4] "MPa" Vector__XXX
 SG_ VDC138_6_0_PRESSURE_WC_FTRH : 48|8@1+ (0.08,0) [0|20.4] "MPa" Vector__XXX
 SG_ VDC138_4_0_YAW_RATE : 32|16@1- (0.0047358121330724,0) [-1.571|1.571] "rad/s"  DAM
 SG_ VDC138_2_0_STEER_ANGLE : 16|16@1- (0.1,0) [-719.9|719.9] "deg"  AHL,DAM,BIU
 SG_ VDC138_1_0_MSG_COUNTER : 8|4@1+ (1,0) [0|15] ""  DAM,BIU
 SG_ VDC138_1_4_ACTIVE_LDP : 12|1@1+ (1,0) [0|1] "" Vector__XXX
 SG_ VDC138_1_5_PROHIBIT_LDP : 13|1@1+ (1,0) [0|1] "" Vector__XXX
 SG_ VDC138_1_6_VDC_SMALL_MARGIN : 14|1@1+ (1,0) [0|1] "" Vector__XXX
 SG_ VDC138_1_7_DETECT_REAR_SLIP : 15|1@1+ (1,0) [0|1] "" Vector__XXX
 SG_ VDC138_0_0_CHECK_SUM : 0|8@1+ (1,0) [0|255] ""  DAM,BIU

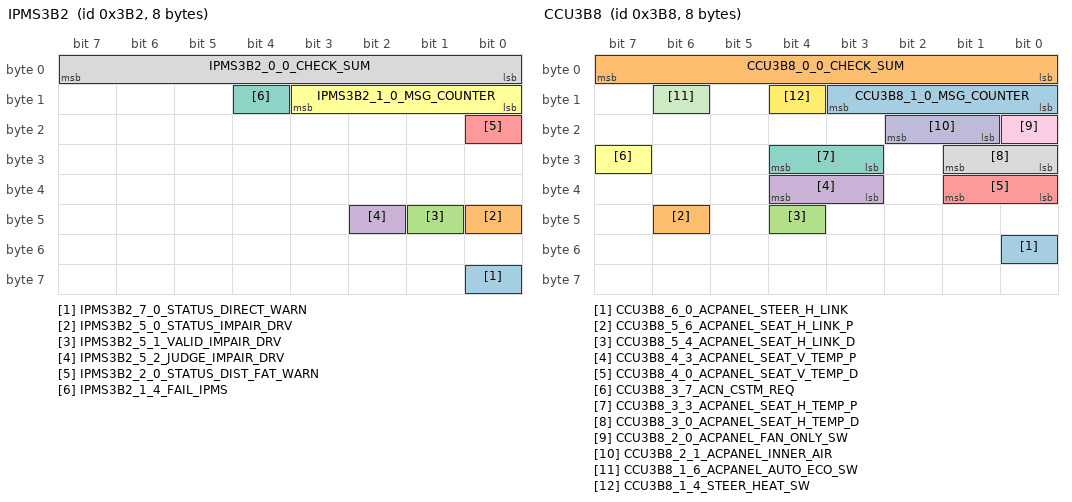
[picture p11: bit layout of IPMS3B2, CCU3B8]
BO_ 946 IPMS3B2: 8 C_ECU_GW
 SG_ IPMS3B2_7_0_STATUS_DIRECT_WARN : 56|1@1+ (1,0) [0|0] "" Vector__XXX
 SG_ IPMS3B2_5_0_STATUS_IMPAIR_DRV : 40|1@1+ (1,0) [0|1] "" Vector__XXX
 SG_ IPMS3B2_5_1_VALID_IMPAIR_DRV : 41|1@1+ (1,0) [0|1] "" Vector__XXX
 SG_ IPMS3B2_5_2_JUDGE_IMPAIR_DRV : 42|1@1+ (1,0) [0|1] "" Vector__XXX
 SG_ IPMS3B2_2_0_STATUS_DIST_FAT_WARN : 16|1@1+ (1,0) [0|1] "" Vector__XXX
 SG_ IPMS3B2_1_0_MSG_COUNTER : 8|4@1+ (1,0) [0|15] "" Vector__XXX
 SG_ IPMS3B2_1_4_FAIL_IPMS : 12|1@1+ (1,0) [0|1] "" Vector__XXX
 SG_ IPMS3B2_0_0_CHECK_SUM : 0|8@1+ (1,0) [0|255] "" Vector__XXX

BO_ 952 CCU3B8: 8 C_ECU_GW
 SG_ CCU3B8_6_0_ACPANEL_STEER_H_LINK : 48|1@1+ (1,0) [0|3] ""  ACN
 SG_ CCU3B8_5_6_ACPANEL_SEAT_H_LINK_P : 46|1@1+ (1,0) [0|3] ""  ACN
 SG_ CCU3B8_5_4_ACPANEL_SEAT_H_LINK_D : 44|1@1+ (1,0) [0|3] ""  ACN
 SG_ CCU3B8_4_3_ACPANEL_SEAT_V_TEMP_P : 35|2@1+ (1,0) [0|3] ""  ACN
 SG_ CCU3B8_4_0_ACPANEL_SEAT_V_TEMP_D : 32|2@1+ (1,0) [0|3] ""  ACN
 SG_ CCU3B8_3_7_ACN_CSTM_REQ : 31|1@1+ (1,0) [0|1] ""  ACN
 SG_ CCU3B8_3_3_ACPANEL_SEAT_H_TEMP_P : 27|2@1+ (1,0) [0|3] ""  ACN
 SG_ CCU3B8_3_0_ACPANEL_SEAT_H_TEMP_D : 24|2@1+ (1,0) [0|3] ""  ACN
 SG_ CCU3B8_2_0_ACPANEL_FAN_ONLY_SW : 16|1@1+ (1,0) [0|3] ""  ACN
 SG_ CCU3B8_2_1_ACPANEL_INNER_AIR : 17|2@1+ (1,0) [0|3] ""  ACN
 SG_ CCU3B8_1_6_ACPANEL_AUTO_ECO_SW : 14|1@1+ (1,0) [0|3] ""  ACN
 SG_ CCU3B8_1_4_STEER_HEAT_SW : 12|1@1+ (1,0) [0|3] ""  ACN
 SG_ CCU3B8_1_0_MSG_COUNTER : 8|4@1+ (1,0) [0|15] ""  ACN
 SG_ CCU3B8_0_0_CHECK_SUM : 0|8@1+ (1,0) [0|255] ""  ACN

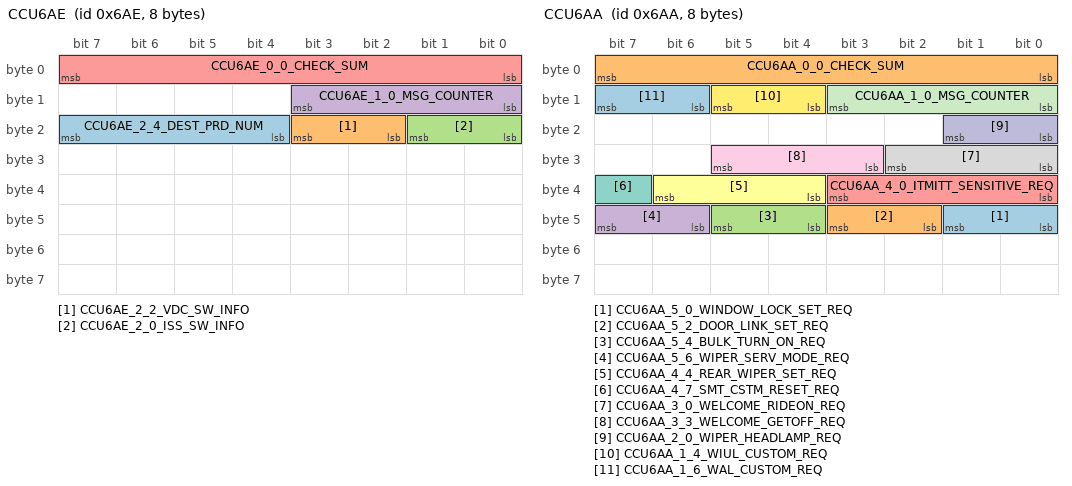
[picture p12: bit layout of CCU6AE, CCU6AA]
BO_ 1710 CCU6AE: 8 C_ECU_GW
 SG_ CCU6AE_2_4_DEST_PRD_NUM : 20|4@1+ (1,0) [0|21] ""  TPM
 SG_ CCU6AE_2_2_VDC_SW_INFO : 18|2@1+ (1,0) [0|2] "" Vector__XXX
 SG_ CCU6AE_2_0_ISS_SW_INFO : 16|2@1+ (1,0) [0|1] "" Vector__XXX
 SG_ CCU6AE_1_0_MSG_COUNTER : 8|4@1+ (1,0) [0|15] ""  TPM
 SG_ CCU6AE_0_0_CHECK_SUM : 0|8@1+ (1,0) [0|255] ""  TPM

BO_ 1707 CCU6AB: 8 C_ECU_GW
 SG_ CCU6AB_7_3_REQ_RESET_CSTM_TPM : 59|1@1+ (1,0) [0|1] ""  TPM
 SG_ CCU6AB_7_2_TPM_CSTM_CHG_REQ : 58|1@1+ (1,0) [0|1] ""  TPM
 SG_ CCU6AB_7_0_CSTM_TIRE_UNIT : 56|2@1+ (1,0) [0|1] ""  TPM
 SG_ CCU6AB_6_3_REQ_RESET_CSTM_AHL : 51|1@1+ (1,0) [0|1] ""  AHL
 SG_ CCU6AB_6_2_SRH_CSTM_CHG_REQ : 50|1@1+ (1,0) [0|1] ""  AHL
 SG_ CCU6AB_6_0_SRH_CSTM_CHG_SET : 48|2@1+ (1,0) [0|1] ""  AHL
 SG_ CCU6AB_5_0_SEATAWAY_DST_CSTM : 40|2@1+ (1,0) [0|3] "" Vector__XXX
 SG_ CCU6AB_5_2_DRIVER_POSI_REQ : 42|4@1+ (1,0) [0|2] "" Vector__XXX
 SG_ CCU6AB_5_6_OCCUPANT_DETECT_REQ : 46|2@1+ (1,0) [0|3] "" Vector__XXX
 SG_ CCU6AB_4_6_AFOLD_SW_MIR_SW : 38|2@1+ (1,0) [0|1] "" Vector__XXX
 SG_ CCU6AB_4_2_MIR_DIRECTION_MIR_SW : 34|4@1+ (1,0) [0|4] "" Vector__XXX
 SG_ CCU6AB_4_0_MIR_SELECT_LR_MIR_SW : 32|2@1+ (1,0) [0|2] "" Vector__XXX
 SG_ CCU6AB_3_0_PRG_OPENER_SW : 24|1@1+ (1,0) [0|1] "" Vector__XXX
 SG_ CCU6AB_3_1_PRG_MEM_CHG_REQ : 25|1@1+ (1,0) [0|1] "" Vector__XXX
 SG_ CCU6AB_3_2_PRG_HF_CHG_REQ : 26|1@1+ (1,0) [0|1] "" Vector__XXX
 SG_ CCU6AB_3_6_MIR_RTILT_R_CSTM : 30|1@1+ (1,0) [0|1] "" Vector__XXX
 SG_ CCU6AB_3_7_MIR_RTILT_L_CSTM : 31|1@1+ (1,0) [0|1] "" Vector__XXX
 SG_ CCU6AB_2_6_WASH_CAR_MODE_REQ : 22|2@1+ (1,0) [0|1] "" Vector__XXX
 SG_ CCU6AB_2_4_SHUT_DOWN_MODE_REQ : 20|2@1+ (1,0) [0|1] "" Vector__XXX
 SG_ CCU6AB_2_2_PET_MODE_SWITCH_REQ : 18|2@1+ (1,0) [0|1] "" Vector__XXX
 SG_ CCU6AB_2_0_POW_ON_FIX_MODE_REQ : 16|2@1+ (1,0) [0|1] "" Vector__XXX
 SG_ CCU6AB_1_7_CECU_CSTM_RESET_REQ : 15|1@1+ (1,0) [0|1] "" Vector__XXX
 SG_ CCU6AB_1_0_MSG_COUNTER : 8|4@1+ (1,0) [0|15] ""  AHL,TPM
 SG_ CCU6AB_0_0_CHECK_SUM : 0|8@1+ (1,0) [0|255] ""  AHL,TPM

BO_ 1706 CCU6AA: 8 C_ECU_GW
 SG_ CCU6AA_5_0_WINDOW_LOCK_SET_REQ : 40|2@1+ (1,0) [0|1] ""  BIU
 SG_ CCU6AA_5_2_DOOR_LINK_SET_REQ : 42|2@1+ (1,0) [0|1] ""  BIU
 SG_ CCU6AA_5_4_BULK_TURN_ON_REQ : 44|2@1+ (1,0) [0|1] "" Vector__XXX
 SG_ CCU6AA_5_6_WIPER_SERV_MODE_REQ : 46|2@1+ (1,0) [0|3] ""  BIU
 SG_ CCU6AA_4_0_ITMITT_SENSITIVE_REQ : 32|4@1+ (1,0) [0|21] ""  BIU
 SG_ CCU6AA_4_4_REAR_WIPER_SET_REQ : 36|3@1+ (1,0) [0|3] ""  BIU
 SG_ CCU6AA_4_7_SMT_CSTM_RESET_REQ : 39|1@1+ (1,0) [0|1] ""  SMT
 SG_ CCU6AA_3_0_WELCOME_RIDEON_REQ : 24|3@1+ (1,0) [0|7] "" Vector__XXX
 SG_ CCU6AA_3_3_WELCOME_GETOFF_REQ : 27|3@1+ (1,0) [0|7] "" Vector__XXX
 SG_ CCU6AA_2_0_WIPER_HEADLAMP_REQ : 16|2@1+ (1,0) [0|3] "" Vector__XXX
 SG_ CCU6AA_1_0_MSG_COUNTER : 8|4@1+ (1,0) [0|15] ""  SMT,BIU
 SG_ CCU6AA_1_4_WIUL_CUSTOM_REQ : 12|2@1+ (1,0) [0|2] ""  SMT
 SG_ CCU6AA_1_6_WAL_CUSTOM_REQ : 14|2@1+ (1,0) [0|2] ""  SMT
 SG_ CCU6AA_0_0_CHECK_SUM : 0|8@1+ (1,0) [0|255] ""  SMT,BIU

BO_ 1704 CCU6A8: 8 C_ECU_GW
 SG_ CCU6A8_7_5_TRQ_CHG_MODE_SET : 61|2@1+ (1,0) [0|3] "" Vector__XXX
 SG_ CCU6A8_7_3_ADAPT_DEC_CHG_REQ : 59|2@1+ (1,0) [0|3] "" Vector__XXX
 SG_ CCU6A8_7_0_DEC_SELECT_REQ_B : 56|3@1+ (1,0) [0|3] "" Vector__XXX
 SG_ CCU6A8_6_5_DEC_SELECT_REQ_D : 53|3@1+ (1,0) [0|3] "" Vector__XXX
 SG_ CCU6A8_6_2_DEC_SELECT_REQ_ALL : 50|3@1+ (1,0) [0|3] "" Vector__XXX
 SG_ CCU6A8_6_0_DEC_SELECT_REQ_IND : 48|2@1+ (1,0) [0|3] "" Vector__XXX
 SG_ CCU6A8_5_2_TOWING_MODE_REQ : 42|2@1+ (1,0) [0|2] "" Vector__XXX
 SG_ CCU6A8_5_0_FACTORY_MODE_STATE : 40|2@1+ (1,0) [0|3] "" Vector__XXX
 SG_ CCU6A8_4_2_TRIP_RESET_REQ : 34|2@1+ (1,0) [0|1] "" Vector__XXX
 SG_ CCU6A8_4_0_TRIP_SWITCH_REQ : 32|2@1+ (1,0) [0|3] "" Vector__XXX
 SG_ CCU6A8_3_0_DOW_SFT_POS_SET : 24|2@1+ (1,0) [0|1] "" Vector__XXX
 SG_ CCU6A8_2_6_DOW_SET : 22|2@1+ (1,0) [0|1] "" Vector__XXX
 SG_ CCU6A8_2_4_RCTA_SET : 20|2@1+ (1,0) [0|1] "" Vector__XXX
 SG_ CCU6A8_2_2_BSD_LCA_2ND_SET : 18|2@1+ (1,0) [0|1] "" Vector__XXX
 SG_ CCU6A8_2_0_SRVD_SET : 16|2@1+ (1,0) [0|1] "" Vector__XXX
 SG_ CCU6A8_1_6_RCR_CSTM_RESET_REQ : 14|1@1+ (1,0) [0|1] "" Vector__XXX
 SG_ CCU6A8_1_4_BEV_CSTM_RESET_REQ : 12|1@1+ (1,0) [0|1] "" Vector__XXX
 SG_ CCU6A8_1_0_MSG_COUNTER : 8|4@1+ (1,0) [0|15] "" Vector__XXX
 SG_ CCU6A8_0_0_CHECK_SUM : 0|8@1+ (1,0) [0|255] "" Vector__XXX

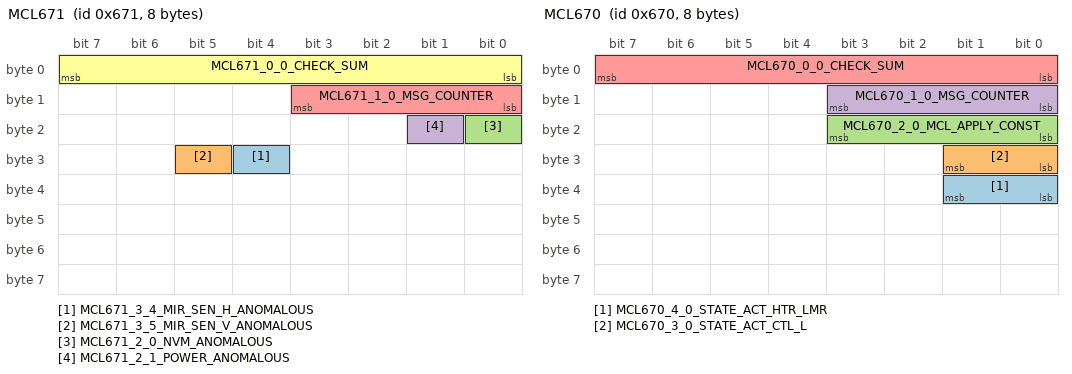
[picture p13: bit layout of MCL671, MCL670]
BO_ 1649 MCL671: 8 MCL
 SG_ MCL671_3_4_MIR_SEN_H_ANOMALOUS : 28|1@0+ (1,0) [0|1] ""  C_ECU
 SG_ MCL671_3_5_MIR_SEN_V_ANOMALOUS : 29|1@0+ (1,0) [0|1] ""  C_ECU
 SG_ MCL671_2_0_NVM_ANOMALOUS : 16|1@0+ (1,0) [0|1] ""  C_ECU
 SG_ MCL671_2_1_POWER_ANOMALOUS : 17|1@0+ (1,0) [0|1] ""  C_ECU
 SG_ MCL671_1_0_MSG_COUNTER : 11|4@0+ (1,0) [0|15] ""  C_ECU
 SG_ MCL671_0_0_CHECK_SUM : 7|8@0+ (1,0) [0|255] ""  C_ECU

BO_ 1648 MCL670: 8 MCL
 SG_ MCL670_4_0_STATE_ACT_HTR_LMR : 33|2@0+ (1,0) [0|3] ""  C_ECU
 SG_ MCL670_3_0_STATE_ACT_CTL_L : 25|2@0+ (1,0) [0|3] ""  C_ECU
 SG_ MCL670_2_0_MCL_APPLY_CONST : 19|4@0+ (1,0) [0|8] ""  C_ECU
 SG_ MCL670_1_0_MSG_COUNTER : 11|4@0+ (1,0) [0|15] ""  C_ECU
 SG_ MCL670_0_0_CHECK_SUM : 7|8@0+ (1,0) [0|255] ""  C_ECU

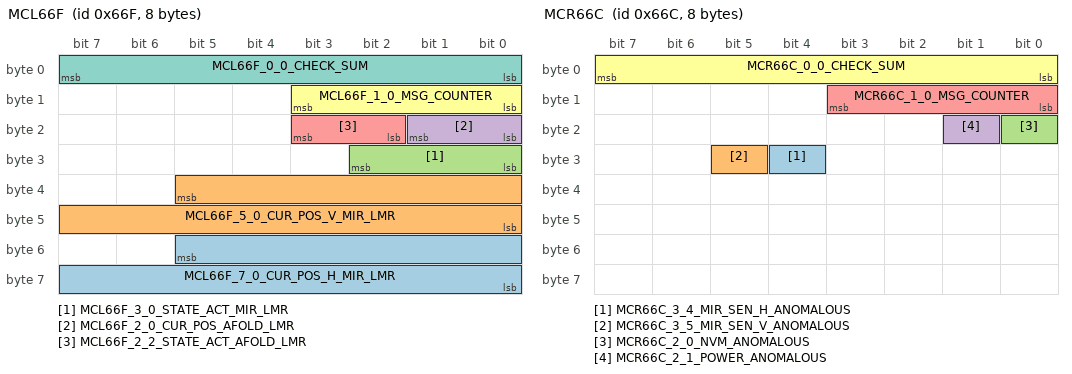
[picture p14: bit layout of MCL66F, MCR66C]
BO_ 1647 MCL66F: 8 MCL
 SG_ MCL66F_7_0_CUR_POS_H_MIR_LMR : 53|14@0+ (1,0) [0|16383] "mV"  C_ECU
 SG_ MCL66F_5_0_CUR_POS_V_MIR_LMR : 37|14@0+ (1,0) [0|16383] "mV"  C_ECU
 SG_ MCL66F_3_0_STATE_ACT_MIR_LMR : 26|3@0+ (1,0) [0|4] ""  C_ECU
 SG_ MCL66F_2_0_CUR_POS_AFOLD_LMR : 17|2@0+ (1,0) [0|3] ""  C_ECU
 SG_ MCL66F_2_2_STATE_ACT_AFOLD_LMR : 19|2@0+ (1,0) [0|3] ""  C_ECU
 SG_ MCL66F_1_0_MSG_COUNTER : 11|4@0+ (1,0) [0|15] ""  C_ECU
 SG_ MCL66F_0_0_CHECK_SUM : 7|8@0+ (1,0) [0|255] ""  C_ECU

BO_ 1644 MCR66C: 8 MCR
 SG_ MCR66C_3_4_MIR_SEN_H_ANOMALOUS : 28|1@0+ (1,0) [0|1] ""  C_ECU
 SG_ MCR66C_3_5_MIR_SEN_V_ANOMALOUS : 29|1@0+ (1,0) [0|1] ""  C_ECU
 SG_ MCR66C_2_0_NVM_ANOMALOUS : 16|1@0+ (1,0) [0|1] ""  C_ECU
 SG_ MCR66C_2_1_POWER_ANOMALOUS : 17|1@0+ (1,0) [0|1] ""  C_ECU
 SG_ MCR66C_1_0_MSG_COUNTER : 11|4@0+ (1,0) [0|15] ""  C_ECU
 SG_ MCR66C_0_0_CHECK_SUM : 7|8@0+ (1,0) [0|255] ""  C_ECU

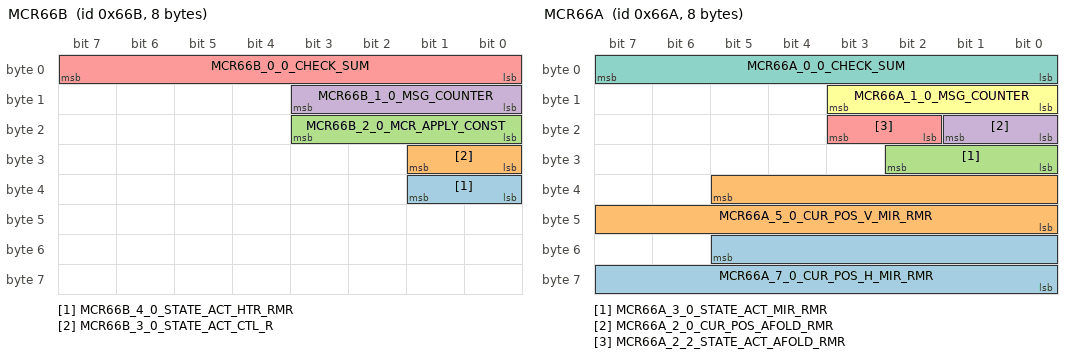
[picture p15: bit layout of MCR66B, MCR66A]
BO_ 1643 MCR66B: 8 MCR
 SG_ MCR66B_4_0_STATE_ACT_HTR_RMR : 33|2@0+ (1,0) [0|3] ""  C_ECU
 SG_ MCR66B_3_0_STATE_ACT_CTL_R : 25|2@0+ (1,0) [0|3] ""  C_ECU
 SG_ MCR66B_2_0_MCR_APPLY_CONST : 19|4@0+ (1,0) [0|8] ""  C_ECU
 SG_ MCR66B_1_0_MSG_COUNTER : 11|4@0+ (1,0) [0|15] ""  C_ECU
 SG_ MCR66B_0_0_CHECK_SUM : 7|8@0+ (1,0) [0|255] ""  C_ECU

BO_ 1642 MCR66A: 8 MCR
 SG_ MCR66A_7_0_CUR_POS_H_MIR_RMR : 53|14@0+ (1,0) [0|16383] "mV"  C_ECU
 SG_ MCR66A_5_0_CUR_POS_V_MIR_RMR : 37|14@0+ (1,0) [0|16383] "mV"  C_ECU
 SG_ MCR66A_3_0_STATE_ACT_MIR_RMR : 26|3@0+ (1,0) [0|4] ""  C_ECU
 SG_ MCR66A_2_0_CUR_POS_AFOLD_RMR : 17|2@0+ (1,0) [0|3] ""  C_ECU
 SG_ MCR66A_2_2_STATE_ACT_AFOLD_RMR : 19|2@0+ (1,0) [0|3] ""  C_ECU
 SG_ MCR66A_1_0_MSG_COUNTER : 11|4@0+ (1,0) [0|15] ""  C_ECU
 SG_ MCR66A_0_0_CHECK_SUM : 7|8@0+ (1,0) [0|255] ""  C_ECU

BO_ 1808 DNT710: 8 C_ECU_GW

BO_ 992 BIU3E0: 8 BIU

BO_ 1665 CECU681: 8 C_ECU
 SG_ CECU681_6_7_DP_CHANGE_SET_REQ : 55|1@1+ (1,0) [0|1] "" Vector__XXX
 SG_ CECU681_6_4_SMT_LINK : 52|1@1+ (1,0) [0|1] "" Vector__XXX
 SG_ CECU681_6_3_IPMS_LINK : 51|1@1+ (1,0) [0|1] "" Vector__XXX
 SG_ CECU681_5_6_DP_DKYMEM_LIST_NO15 : 46|1@1+ (1,0) [0|1] "" Vector__XXX
 SG_ CECU681_5_5_DP_DKYMEM_LIST_NO14 : 45|1@1+ (1,0) [0|1] "" Vector__XXX
 SG_ CECU681_5_4_DP_DKYMEM_LIST_NO13 : 44|1@1+ (1,0) [0|1] "" Vector__XXX
 SG_ CECU681_5_3_DP_DKYMEM_LIST_NO12 : 43|1@1+ (1,0) [0|1] "" Vector__XXX
 SG_ CECU681_5_2_DP_DKYMEM_LIST_NO11 : 42|1@1+ (1,0) [0|1] "" Vector__XXX
 SG_ CECU681_5_1_DP_DKYMEM_LIST_NO10 : 41|1@1+ (1,0) [0|1] "" Vector__XXX
 SG_ CECU681_5_0_DP_DKYMEM_LIST_NO9 : 40|1@1+ (1,0) [0|1] "" Vector__XXX
 SG_ CECU681_4_7_DP_DKYMEM_LIST_NO8 : 39|1@1+ (1,0) [0|1] "" Vector__XXX
 SG_ CECU681_4_6_DP_DKYMEM_LIST_NO7 : 38|1@1+ (1,0) [0|1] "" Vector__XXX
 SG_ CECU681_4_5_DP_DKYMEM_LIST_NO6 : 37|1@1+ (1,0) [0|1] "" Vector__XXX
 SG_ CECU681_4_4_DP_DKYMEM_LIST_NO5 : 36|1@1+ (1,0) [0|1] "" Vector__XXX
 SG_ CECU681_4_3_DP_DKYMEM_LIST_NO4 : 35|1@1+ (1,0) [0|1] "" Vector__XXX
 SG_ CECU681_4_2_DP_DKYMEM_LIST_NO3 : 34|1@1+ (1,0) [0|1] "" Vector__XXX
 SG_ CECU681_4_1_DP_DKYMEM_LIST_NO2 : 33|1@1+ (1,0) [0|1] "" Vector__XXX
 SG_ CECU681_4_0_DP_DKYMEM_LIST_NO1 : 32|1@1+ (1,0) [0|1] "" Vector__XXX
 SG_ CECU681_3_5_RECOG_FACTOR : 29|3@1+ (1,0) [0|7] ""  ACN
 SG_ CECU681_3_4_RECOG_USER_VALIDFRAG : 28|1@1+ (1,0) [0|1] ""  ACN
 SG_ CECU681_3_0_RESULT_NOTICE_REQ : 24|4@1+ (1,0) [0|15] "" Vector__XXX
 SG_ CECU681_2_4_RECOG_USER_NO : 20|4@1+ (1,0) [0|15] ""  ACN
 SG_ CECU681_2_0_POPUP_NOTICE_NO : 16|4@1+ (1,0) [0|15] "" Vector__XXX
 SG_ CECU681_1_7_DP_FAILE_FRAG : 15|1@1+ (1,0) [0|1] "" Vector__XXX
 SG_ CECU681_1_5_DP_PROCESS_RESULT : 13|2@1+ (1,0) [0|3] "" Vector__XXX
 SG_ CECU681_1_4_POPUP_NOTICE_REQ : 12|1@1+ (1,0) [0|1] "" Vector__XXX
 SG_ CECU681_1_0_MSG_COUNTER : 8|4@1+ (1,0) [0|15] ""  ACN
 SG_ CECU681_0_0_CHECK_SUM : 0|8@1+ (1,0) [0|255] ""  ACN

BO_ 1610 SMT64A: 8 SMT
 SG_ SMT64A_1_0_IADKCD : 8|56@1+ (1,0) [0|7.2057594037928E+16] ""  DKY
 SG_ SMT64A_0_0_RGMDDK1 : 0|8@1+ (1,0) [0|40] ""  DKY

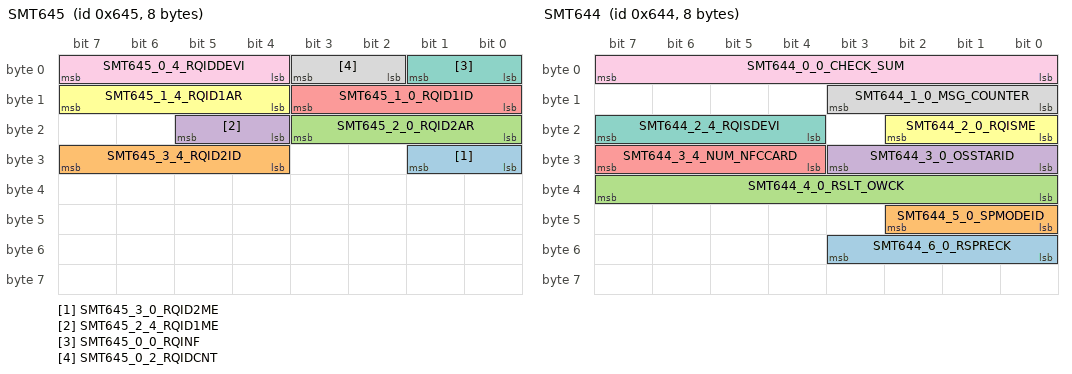
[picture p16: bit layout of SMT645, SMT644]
BO_ 1605 SMT645: 8 SMT
 SG_ SMT645_3_0_RQID2ME : 24|2@1+ (1,0) [0|3] ""  DKY
 SG_ SMT645_3_4_RQID2ID : 28|4@1+ (1,0) [0|15] ""  DKY
 SG_ SMT645_2_0_RQID2AR : 16|4@1+ (1,0) [0|11] ""  DKY
 SG_ SMT645_2_4_RQID1ME : 20|2@1+ (1,0) [0|3] ""  DKY
 SG_ SMT645_1_0_RQID1ID : 8|4@1+ (1,0) [0|15] ""  DKY
 SG_ SMT645_1_4_RQID1AR : 12|4@1+ (1,0) [0|11] ""  DKY
 SG_ SMT645_0_0_RQINF : 0|2@1+ (1,0) [0|3] ""  DKY
 SG_ SMT645_0_2_RQIDCNT : 2|2@1+ (1,0) [0|3] ""  DKY
 SG_ SMT645_0_4_RQIDDEVI : 4|4@1+ (1,0) [0|2] ""  DKY

BO_ 1604 SMT644: 8 SMT
 SG_ SMT644_6_0_RSPRECK : 48|4@1+ (1,0) [0|5] ""  C_ECU
 SG_ SMT644_5_0_SPMODEID : 40|3@1+ (1,0) [0|4] ""  C_ECU
 SG_ SMT644_4_0_RSLT_OWCK : 32|8@1+ (1,0) [0|63] ""  C_ECU
 SG_ SMT644_3_0_OSSTARID : 24|4@1+ (1,0) [0|15] ""  DKY
 SG_ SMT644_3_4_NUM_NFCCARD : 28|4@1+ (1,0) [0|4] ""  C_ECU
 SG_ SMT644_2_0_RQISME : 16|3@1+ (1,0) [0|7] ""  DKY
 SG_ SMT644_2_4_RQISDEVI : 20|4@1+ (1,0) [0|2] ""  DKY
 SG_ SMT644_1_0_MSG_COUNTER : 8|4@1+ (1,0) [0|15] ""  C_ECU
 SG_ SMT644_0_0_CHECK_SUM : 0|8@1+ (1,0) [0|255] ""  C_ECU

BO_ 1583 SMT62F: 8 SMT
 SG_ SMT62F_0_0_D_IADK4 : 0|64@0+ (1,0) [0|1.844674407371E+19] ""  DKY

BO_ 1582 SMT62E: 8 SMT
 SG_ SMT62E_0_0_D_IADK3 : 0|64@0+ (1,0) [0|1.844674407371E+19] ""  DKY

BO_ 1581 SMT62D: 8 SMT
 SG_ SMT62D_0_0_D_IADK2 : 0|64@0+ (1,0) [0|1.844674407371E+19] ""  DKY

BO_ 1580 SMT62C: 8 SMT
 SG_ SMT62C_0_0_D_IADK1 : 0|64@0+ (1,0) [0|1.844674407371E+19] ""  DKY

BO_ 1579 SMT62B: 8 SMT
 SG_ SMT62B_0_0_FVIADK1 : 0|64@0+ (1,0) [0|1.844674407371E+19] ""  DKY

BO_ 1578 SMT62A: 8 SMT
 SG_ SMT62A_0_0_FVIADK1 : 0|64@0+ (1,0) [0|1.844674407371E+19] ""  DKY

BO_ 1816 DKY718: 8 DKY

BO_ 1820 DKY71C: 8 DKY
 SG_ DKY71C_DIAG_DATA : 7|64@0+ (1,0) [0|1.844674407371E+19] ""  C_ECU

BO_ 1812 CECU714: 8 C_ECU
 SG_ CECU714_DIAG_DATA : 7|64@0+ (1,0) [0|1.844674407371E+19] ""  DKY

BO_ 1313 DKY521: 8 DKY
 SG_ DKY521_1_4_ActiveWakeUpBit : 12|1@1+ (1,0) [0|1] ""  C_ECU
 SG_ DKY521_0_0_SourceNodeID : 0|8@1+ (1,0) [0|255] ""  C_ECU

BO_ 1613 DKY64D: 8 DKY
 SG_ DKY64D_1_0_BLESRNO2 : 8|56@1+ (1,0) [0|7.2057594037928E+16] ""  C_ECU_GW
 SG_ DKY64D_0_0_BLESNO1 : 0|5@1+ (1,0) [0|31] ""  C_ECU_GW
 SG_ DKY64D_0_5_BLEMSGID : 5|3@1+ (1,0) [0|5] ""  C_ECU_GW

BO_ 1612 DKY64C: 8 DKY
 SG_ DKY64C_5_0_DKY_ID : 40|4@1+ (1,0) [0|15] ""  C_ECU,C_ECU_GW
 SG_ DKY64C_5_6_DKY_RSLT : 46|2@1+ (1,0) [0|3] ""  C_ECU,C_ECU_GW
 SG_ DKY64C_4_0_RSRGDK : 32|8@1+ (1,0) [0|54] ""  C_ECU,C_ECU_GW
 SG_ DKY64C_2_0_DKYSID : 16|16@1+ (1,0) [0|65535] ""  C_ECU,C_ECU_GW
 SG_ DKY64C_0_0_DKRGNGFC : 0|16@1+ (1,0) [0|132] ""  C_ECU,C_ECU_GW

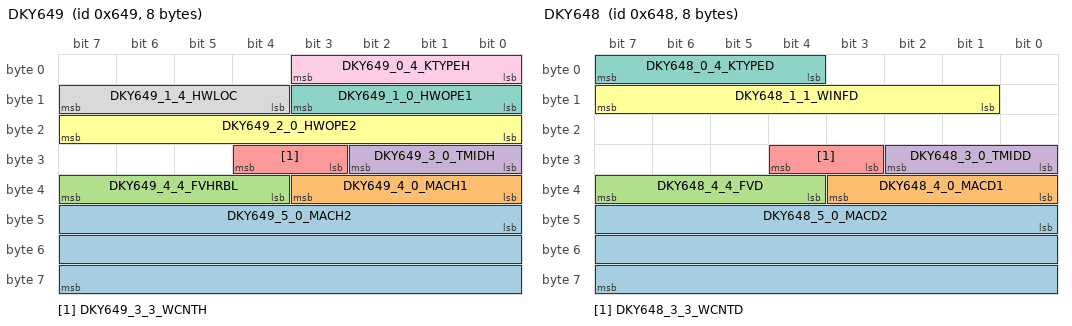
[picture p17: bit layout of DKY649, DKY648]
BO_ 1609 DKY649: 8 DKY
 SG_ DKY649_5_0_MACH2 : 40|24@1+ (1,0) [0|16777215] ""  SMT
 SG_ DKY649_4_0_MACH1 : 32|4@1+ (1,0) [0|15] ""  SMT
 SG_ DKY649_4_4_FVHRBL : 36|4@1+ (1,0) [0|15] ""  SMT
 SG_ DKY649_3_0_TMIDH : 24|3@1+ (1,0) [0|7] ""  SMT
 SG_ DKY649_3_3_WCNTH : 27|2@1+ (1,0) [0|3] ""  SMT
 SG_ DKY649_2_0_HWOPE2 : 16|8@1+ (1,0) [0|192] ""  SMT
 SG_ DKY649_1_0_HWOPE1 : 8|4@1+ (1,0) [0|8] ""  SMT
 SG_ DKY649_1_4_HWLOC : 12|4@1+ (1,0) [0|7] ""  SMT
 SG_ DKY649_0_4_KTYPEH : 0|4@1+ (1,0) [0|2] ""  SMT

BO_ 1608 DKY648: 8 DKY
 SG_ DKY648_5_0_MACD2 : 40|24@1+ (1,0) [0|16777215] ""  SMT,C_ECU_GW
 SG_ DKY648_4_0_MACD1 : 32|4@1+ (1,0) [0|15] ""  SMT,C_ECU_GW
 SG_ DKY648_4_4_FVD : 36|4@1+ (1,0) [0|15] ""  SMT,C_ECU_GW
 SG_ DKY648_3_0_TMIDD : 24|3@1+ (1,0) [0|7] ""  SMT,C_ECU_GW
 SG_ DKY648_3_3_WCNTD : 27|2@1+ (1,0) [0|3] ""  SMT,C_ECU_GW
 SG_ DKY648_1_1_WINFD : 9|7@1+ (1,0) [0|32] ""  SMT,C_ECU_GW
 SG_ DKY648_0_4_KTYPED : 4|4@1+ (1,0) [0|14] ""  SMT,C_ECU_GW

BO_ 982 DKY3D6: 8 DKY

BO_ 1013 DKY3F5: 8 DKY

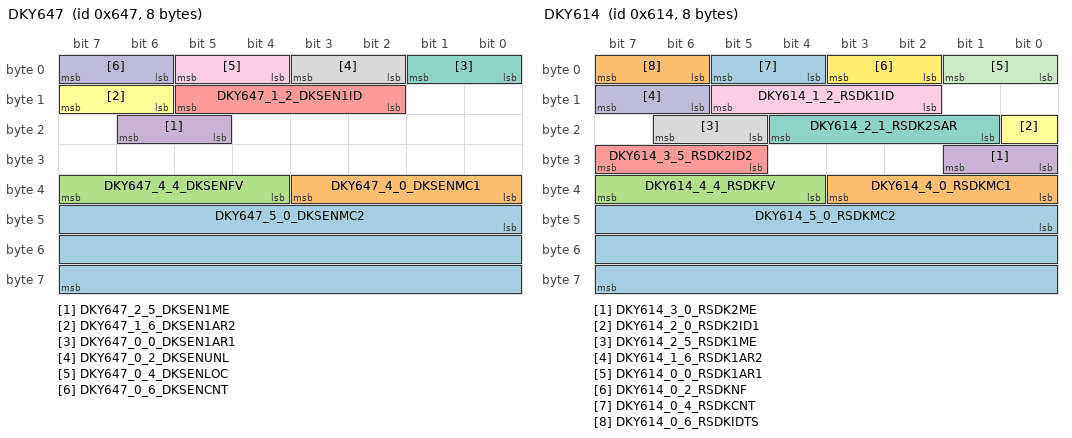
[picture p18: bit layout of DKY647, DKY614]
BO_ 1607 DKY647: 8 DKY
 SG_ DKY647_5_0_DKSENMC2 : 40|24@1+ (1,0) [0|16777215] ""  SMT
 SG_ DKY647_4_0_DKSENMC1 : 32|4@1+ (1,0) [0|15] ""  SMT
 SG_ DKY647_4_4_DKSENFV : 36|4@1+ (1,0) [0|15] ""  SMT
 SG_ DKY647_2_5_DKSEN1ME : 21|2@1+ (1,0) [0|3] ""  SMT
 SG_ DKY647_1_2_DKSEN1ID : 10|4@1+ (1,0) [0|15] "" Vector__XXX
 SG_ DKY647_1_6_DKSEN1AR2 : 14|2@1+ (1,0) [0|3] ""  SMT
 SG_ DKY647_0_0_DKSEN1AR1 : 0|2@1+ (1,0) [0|14] ""  SMT
 SG_ DKY647_0_2_DKSENUNL : 2|2@1+ (1,0) [0|14] ""  SMT
 SG_ DKY647_0_4_DKSENLOC : 4|2@1+ (1,0) [0|14] ""  SMT
 SG_ DKY647_0_6_DKSENCNT : 6|2@1+ (1,0) [0|3] ""  SMT

BO_ 1737 DKY6C9: 8 DKY
 SG_ DKY6C9_0_0_DKIACD : 0|64@1+ (1,0) [0|1.844674407371E+19] ""  SMT

BO_ 1575 DKY627: 8 DKY
 SG_ DKY627_6_0_SDRGT : 48|16@1+ (1,0) [0|65535] ""  C_ECU,C_ECU_GW
 SG_ DKY627_2_0_FRNDFDEOUT : 16|16@1+ (1,0) [0|65535] ""  C_ECU_GW
 SG_ DKY627_0_5_SPNUM : 5|3@1+ (1,0) [0|4] ""  SMT,C_ECU_GW

BO_ 1574 DKY626: 8 DKY
 SG_ DKY626_2_5_PS_OPSTD : 21|3@1+ (1,0) [0|6] ""  SMT

BO_ 1573 DKY625: 8 DKY
 SG_ DKY625_0_6_DK_REGST : 6|2@1+ (1,0) [0|3] ""  C_ECU

BO_ 1571 DKY623: 8 DKY
 SG_ DKY623_1_3_SPMDEDK : 11|3@1+ (1,0) [0|6] ""  SMT,C_ECU
 SG_ DKY623_0_2_DKINDCST : 2|1@1+ (1,0) [0|1] ""  SMT,C_ECU
 SG_ DKY623_0_4_BZRQ_DK : 4|4@1+ (1,0) [0|1] ""  SMT

BO_ 1565 DKY61D: 8 DKY
 SG_ DKY61D_0_0_D_DKIA7 : 0|64@1+ (1,0) [0|1.844674407371E+19] ""  SMT

BO_ 1564 DKY61C: 8 DKY
 SG_ DKY61C_0_0_D_DKIA6 : 0|64@1+ (1,0) [0|1.844674407371E+19] ""  SMT

BO_ 1563 DKY61B: 8 DKY
 SG_ DKY61B_0_0_D_DKIA5 : 0|64@1+ (1,0) [0|1.844674407371E+19] ""  SMT

BO_ 1562 DKY61A: 8 DKY
 SG_ DKY61A_0_0_D_DKIA4 : 0|64@1+ (1,0) [0|1.844674407371E+19] ""  SMT

BO_ 1561 DKY619: 8 DKY
 SG_ DKY619_0_0_D_DKIA3 : 0|64@1+ (1,0) [0|1.844674407371E+19] ""  SMT

BO_ 1560 DKY618: 8 DKY
 SG_ DKY618_0_0_D_DKIA2 : 0|64@1+ (1,0) [0|1.844674407371E+19] ""  SMT

BO_ 1559 DKY617: 8 DKY
 SG_ DKY617_0_0_D_DKIA1 : 0|64@1+ (1,0) [0|1.844674407371E+19] ""  SMT

BO_ 1558 DKY616: 8 DKY
 SG_ DKY616_0_0_FVDKIA1 : 0|64@0+ (1,0) [0|1.844674407371E+19] ""  SMT

BO_ 1557 DKY615: 8 DKY
 SG_ DKY615_0_0_FVDKIA0 : 0|64@0+ (1,0) [0|1.844674407371E+19] ""  SMT

BO_ 1556 DKY614: 8 DKY
 SG_ DKY614_5_0_RSDKMC2 : 40|24@1+ (1,0) [0|16777215] ""  SMT
 SG_ DKY614_4_0_RSDKMC1 : 32|4@1+ (1,0) [0|15] ""  SMT
 SG_ DKY614_4_4_RSDKFV : 36|4@1+ (1,0) [0|15] ""  SMT
 SG_ DKY614_3_0_RSDK2ME : 24|2@1+ (1,0) [0|3] ""  SMT
 SG_ DKY614_3_5_RSDK2ID2 : 29|3@1+ (1,0) [0|7] ""  SMT
 SG_ DKY614_2_0_RSDK2ID1 : 16|1@1+ (1,0) [0|1] ""  SMT
 SG_ DKY614_2_1_RSDK2SAR : 17|4@1+ (1,0) [0|11] ""  SMT
 SG_ DKY614_2_5_RSDK1ME : 21|2@1+ (1,0) [0|3] ""  SMT
 SG_ DKY614_1_2_RSDK1ID : 10|4@1+ (1,0) [0|15] ""  SMT
 SG_ DKY614_1_6_RSDK1AR2 : 14|2@1+ (1,0) [0|3] ""  SMT
 SG_ DKY614_0_0_RSDK1AR1 : 0|2@1+ (1,0) [0|3] ""  SMT
 SG_ DKY614_0_2_RSDKNF : 2|2@1+ (1,0) [0|3] ""  SMT
 SG_ DKY614_0_4_RSDKCNT : 4|2@1+ (1,0) [0|3] ""  SMT
 SG_ DKY614_0_6_RSDKIDTS : 6|2@1+ (1,0) [0|3] ""  SMT

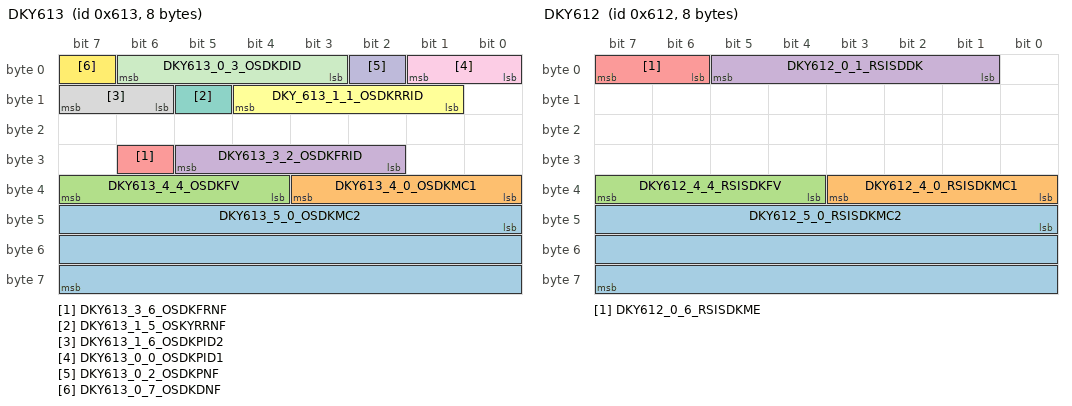
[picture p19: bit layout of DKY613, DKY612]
BO_ 1555 DKY613: 8 DKY
 SG_ DKY613_5_0_OSDKMC2 : 40|24@1+ (1,0) [0|16777215] ""  SMT
 SG_ DKY613_4_0_OSDKMC1 : 32|4@1+ (1,0) [0|15] ""  SMT
 SG_ DKY613_4_4_OSDKFV : 36|4@1+ (1,0) [0|15] ""  SMT
 SG_ DKY613_3_2_OSDKFRID : 26|4@1+ (1,0) [0|15] ""  SMT
 SG_ DKY613_3_6_OSDKFRNF : 30|1@1+ (1,0) [0|1] ""  SMT
 SG_ DKY_613_1_1_OSDKRRID : 9|4@1+ (1,0) [0|15] ""  SMT
 SG_ DKY613_1_5_OSKYRRNF : 13|1@1+ (1,0) [0|1] ""  SMT
 SG_ DKY613_1_6_OSDKPID2 : 14|2@1+ (1,0) [0|3] ""  SMT
 SG_ DKY613_0_0_OSDKPID1 : 0|2@1+ (1,0) [0|3] ""  SMT
 SG_ DKY613_0_2_OSDKPNF : 2|1@1+ (1,0) [0|1] ""  SMT
 SG_ DKY613_0_3_OSDKDID : 3|4@1+ (1,0) [0|15] ""  SMT
 SG_ DKY613_0_7_OSDKDNF : 7|1@1+ (1,0) [0|1] ""  SMT

BO_ 1554 DKY612: 8 DKY
 SG_ DKY612_5_0_RSISDKMC2 : 40|24@1+ (1,0) [0|16777215] ""  SMT
 SG_ DKY612_4_0_RSISDKMC1 : 32|4@1+ (1,0) [0|15] ""  SMT
 SG_ DKY612_4_4_RSISDKFV : 36|4@1+ (1,0) [0|15] ""  SMT
 SG_ DKY612_0_1_RSISDDK : 1|5@1+ (1,0) [0|20] ""  SMT
 SG_ DKY612_0_6_RSISDKME : 6|2@1+ (1,0) [0|3] ""  SMT

CM_ SG_ 948 ACN3B4_2_0_AMB_AC "外気温(A/C)
";
CM_ SG_ 948 ACN3B4_1_0_MSG_COUNTER "ﾒｯｾｰｼﾞｶｳﾝﾀ
";
CM_ SG_ 948 ACN3B4_0_0_CHECK_SUM "ﾁｪｯｸｻﾑ
";
CM_ SG_ 1005 AVN3ED_7_0_ACPANEL_PA_TEMP_DIAL "ｴｱｺﾝﾊﾟﾈﾙ P席TEMP ダイヤルSW情報
";
CM_ SG_ 1005 AVN3ED_7_3_ACPANEL_DR_TEMP_DIAL "ｴｱｺﾝﾊﾟﾈﾙ D席TEMP ダイヤルSW情報
";
CM_ SG_ 1005 AVN3ED_1_0_MSG_COUNTER "ﾒｯｾｰｼﾞｶｳﾝﾀ
";
CM_ SG_ 1005 AVN3ED_0_0_CHECK_SUM "ﾁｪｯｸｻﾑ
";
CM_ SG_ 1723 AVN6BB_7_0_ISA_IACC_OFFSET_CSTM "ISA制限車速・iACCセット車速オフセット値
";
CM_ SG_ 1723 AVN6BB_7_5_EYE_TOLLBOOTH_DECEL "料金所減速ｶｽﾀﾏｲｽﾞ(高度運転支援)
";
CM_ SG_ 1723 AVN6BB_7_6_EYE_CURVE_DECEL_CSTM "カーブ減速ｶｽﾀﾏｲｽﾞ（高度運転支援）
";
CM_ SG_ 1723 AVN6BB_7_7_EYE_GREEN_LIGHT_CSTM "青信号切り替わりお知らせ設定
";
CM_ SG_ 1723 AVN6BB_6_0_CCU_FAIL "CCU/CIDﾌｪｰﾙﾌﾗｸﾞ
";
CM_ SG_ 1723 AVN6BB_6_1_EYE_P_CR_CSTM "P-CR ON/OFF設定
";
CM_ SG_ 1723 AVN6BB_6_2_EYE_ALK_B_LDW_CSTM "車線逸脱防止+車線逸脱警報 ON/OFF設定
";
CM_ SG_ 1723 AVN6BB_6_4_EYE_CSTM_REQ "EyeSightｶｽﾀﾏｲｽﾞ変更要求
";
CM_ SG_ 1723 AVN6BB_6_5_EYE_ELK_CSTM "ELK ON/OFF設定
";
CM_ SG_ 1723 AVN6BB_6_6_EYE_ALKB_EDGE_CSTM "ﾛｰﾄﾞｴｯｼﾞALKBｶｽﾀﾏｲｽﾞ（ALKの制御種別）
";
CM_ SG_ 1723 AVN6BB_6_7_FCW_ON_OFF "FCW機能 ON/OFF設定
";
CM_ SG_ 1723 AVN6BB_5_0_DMS_SELECT_ID "DMS選択ID
";
CM_ SG_ 1723 AVN6BB_5_4_TPMS_TH_MODE_CSTM "TPMS閾値ﾓｰﾄﾞｶｽﾀﾏｲｽﾞ
";
CM_ SG_ 1723 AVN6BB_5_6_DMS_SET_REQ "DMS設定変更要求ﾌﾗｸﾞ
";
CM_ SG_ 1723 AVN6BB_5_7_DMS_RECOG_SET "DMS個人認識ON/OFF設定
";
CM_ SG_ 1723 AVN6BB_4_0_DMS_EDIT_REQ "DMS操作中ﾌﾗｸﾞ
";
CM_ SG_ 1723 AVN6BB_4_4_VEHICLE_DEMO "車両連携デモモード（DMSなど）
";
CM_ SG_ 1723 AVN6BB_4_5_SRVD_CSTM_REQ "SRVDｶｽﾀﾏｲｽﾞ変更要求
";
CM_ SG_ 1723 AVN6BB_4_6_SEAT_RESET_REQ "ｼｰﾄｶｽﾀﾏｲｽﾞﾘｾｯﾄ要求
";
CM_ SG_ 1723 AVN6BB_4_7_SEATAWAY_SET_CSTM "ｼｰﾄ後退設定変更要求
";
CM_ SG_ 1723 AVN6BB_3_0_SRVD_ON_OFF "SRVD ON/OFF SW情報
";
CM_ SG_ 1723 AVN6BB_3_1_PRG_RESET_REQ "PRGｶｽﾀﾏｲｽﾞﾘｾｯﾄ要求
";
CM_ SG_ 1723 AVN6BB_3_2_PRG_MEM_CSTM "PRGﾒﾓﾘ設定変更要求
";
CM_ SG_ 1723 AVN6BB_3_3_DMS_ON_OFF "DMS ON/OFF SW情報
";
CM_ SG_ 1723 AVN6BB_3_4_MIR_RESET_REQ "ﾄﾞｱﾐﾗｰｶｽﾀﾏｲｽﾞﾘｾｯﾄ要求
";
CM_ SG_ 1723 AVN6BB_3_5_MIR_AFOLD_CSTM "ｵｰﾄ電動格納ﾄﾞｱﾐﾗｰ設定変更要求
";
CM_ SG_ 1723 AVN6BB_3_6_MIR_RTILT_CSTM "ﾘﾊﾞｰｽ連動ﾄﾞｱﾐﾗｰ設定変更要求
";
CM_ SG_ 1723 AVN6BB_3_7_EYE_TSA_CSTM "標識認識連動TSA（ISA/iACC） ON/OFF設定
";
CM_ SG_ 1723 AVN6BB_2_0_AVH_ON_OFF "AVH ON/OFF SW情報
";
CM_ SG_ 1723 AVN6BB_2_2_VDC_ON_OFF "VDC ON/OFF 情報
";
CM_ SG_ 1723 AVN6BB_2_4_CCU_HALT_RESET "CCUリセット・一時停止フラグ
";
CM_ SG_ 1723 AVN6BB_2_5_EYE_LDW_TIMING_CSTM "LDWタイミングユーザ設定値
";
CM_ SG_ 1723 AVN6BB_2_6_FCW_CSTM "FCWカスタマイズ設定
";
CM_ SG_ 1723 AVN6BB_1_0_MSG_COUNTER "ﾒｯｾｰｼﾞｶｳﾝﾀ
";
CM_ SG_ 1723 AVN6BB_1_4_EYE_WARN_CSTM "ｽﾃｱ振動ｶｽﾀﾏｲｽﾞ
";
CM_ SG_ 1723 AVN6BB_1_5_EYE_FCTI_CSTM "FCTI(交差車両接近通知)
";
CM_ SG_ 1723 AVN6BB_1_7_LDW_WARNING_ON_OFF "LDW音 ON/OFF設定
";
CM_ SG_ 1723 AVN6BB_0_0_CHECK_SUM "ﾁｪｯｸｻﾑ
";
CM_ SG_ 1722 AVN6BA_7_0_GUIDE_LINE_REAR "Rカメラガイド線表示設定(ON/OFF)
";
CM_ SG_ 1722 AVN6BA_7_1_GUIDE_LINE_SIDE "Sカメラガイド線表示設定(ON/OFF)
";
CM_ SG_ 1722 AVN6BA_7_2_GUIDE_LINE_FRONT "Fカメラガイド線表示設定(ON/OFF)
";
CM_ SG_ 1722 AVN6BA_7_3_STEER_ANGLE_INTERLOCK "Rカメラガイド線舵角連動設定(連動/固定)
";
CM_ SG_ 1722 AVN6BA_7_4_BACK_CAMERA_DELAY "Rカメラ9秒Delay表示設定(ON/OFF)
";
CM_ SG_ 1722 AVN6BA_7_5_REQ_STOP_CAMERA_OUT "カメラ映像出力停止要求フラグ
";
CM_ SG_ 1722 AVN6BA_7_6_VIEW_CHANGE_SW "カメラ切替SW信号
";
CM_ SG_ 1722 AVN6BA_6_0_CLIMAITE_PA_TEMP "音声認識ｴｱｺﾝ Pa_TEMP
";
CM_ SG_ 1722 AVN6BA_6_6_CLIMATE_SYNC "ｴｱｺﾝﾊﾟﾈﾙ SYNC SW
";
CM_ SG_ 1722 AVN6BA_6_7_CLIMATE_F_DEF "Front DEF SW
";
CM_ SG_ 1722 AVN6BA_5_0_CLIMAITE_DR_TEMP "音声認識ｴｱｺﾝ Dr_TEMP
";
CM_ SG_ 1722 AVN6BA_5_6_CLIMAITE_AUTO "音声認識ｴｱｺﾝ AUTO SW
";
CM_ SG_ 1722 AVN6BA_5_7_CLIMAITE_MAX_AC "音声認識ｴｱｺﾝ MAX A/C SW
";
CM_ SG_ 1722 AVN6BA_4_0_CLIMAITE_VR "音声認識ｴｱｺﾝ操作ﾌﾗｸﾞ
";
CM_ SG_ 1722 AVN6BA_4_3_CLIMATE_AC "ｴｱｺﾝﾊﾟﾈﾙ A/C SW
";
CM_ SG_ 1722 AVN6BA_4_4_CLIMAITE_FAN "音声認識ｴｱｺﾝ FAN
";
CM_ SG_ 1722 AVN6BA_3_0_PERSONAL_IC_SH "ﾊﾟｰｿﾅﾗｲｽﾞ：H/Unit（ｽﾏｰﾄﾌｫﾝ無し時）による個人識別ｺｰﾄﾞ
";
CM_ SG_ 1722 AVN6BA_3_4_CSTM_SONNER "ｿﾅｰｶｽﾀﾏｲｽﾞ変更設定(ｿﾅｰ ON/OFF)
";
CM_ SG_ 1722 AVN6BA_3_5_CSTM_RAB "ｿﾅｰｶｽﾀﾏｲｽﾞ変更設定(RAB　ON/OFF)
";
CM_ SG_ 1722 AVN6BA_3_6_REQ_CHG_CSTM_RAB "RABｿﾅｰｶｽﾀﾏｲｽﾞ要求変更
";
CM_ SG_ 1722 AVN6BA_3_7_CLIMATE_R_DEF "Rear DEF SW
";
CM_ SG_ 1722 AVN6BA_2_0_CLIMATE_PTC "ｴｱｺﾝﾊﾟﾈﾙ PTC 強制ON SW
";
CM_ SG_ 1722 AVN6BA_2_1_CLIMATE_MODE "ｴｱｺﾝﾊﾟﾈﾙ MODE SW
";
CM_ SG_ 1722 AVN6BA_2_2_CLIMATE_SEAT_C_L "ｴｱｺﾝﾊﾟﾈﾙ ﾍﾞﾝﾁﾚｰｼｮﾝｼｰﾄ左 SW
";
CM_ SG_ 1722 AVN6BA_2_3_CLIMATE_SEAT_C_R "ｴｱｺﾝﾊﾟﾈﾙ ﾍﾞﾝﾁﾚｰｼｮﾝｼｰﾄ右 SW
";
CM_ SG_ 1722 AVN6BA_2_4_CLIMATE_SEAT_H_L "ｴｱｺﾝﾊﾟﾈﾙ SEAT HEATER左 SW
";
CM_ SG_ 1722 AVN6BA_2_5_CLIMATE_SEAT_H_R "ｴｱｺﾝﾊﾟﾈﾙ SEAT HEATER右 SW
";
CM_ SG_ 1722 AVN6BA_2_6_CLIMATE_INNER_AIR "ｴｱｺﾝﾊﾟﾈﾙ 内外気 SW
";
CM_ SG_ 1722 AVN6BA_2_7_CLIMATE_ON_OFF "ｴｱｺﾝﾊﾟﾈﾙ 空調ON/OFF SW
";
CM_ SG_ 1722 AVN6BA_1_0_MSG_COUNTER "ﾒｯｾｰｼﾞｶｳﾝﾀ
";
CM_ SG_ 1722 AVN6BA_1_4_CLIMAITE_STATUS "音声認識状態表示
";
CM_ SG_ 1722 AVN6BA_1_7_CLIMAITE_ON_OFF "音声認識 ON/OFF
";
CM_ SG_ 1722 AVN6BA_0_0_CHECK_SUM "ﾁｪｯｸｻﾑ
";
CM_ SG_ 1019 AVN3FB_7_0_SMT_TIM_RESET_REQ "自動ｴﾝｼﾞﾝ停止ﾀｲﾏﾘｾｯﾄ要求
";
CM_ SG_ 1019 AVN3FB_7_1_SMT_EG_CSTM_REQ "自動ｴﾝｼﾞﾝ停止カスタマイズ変更要求
";
CM_ SG_ 1019 AVN3FB_7_2_EYE_YEILD_CSTM "特殊標識表示ON/OFF設定（前方優先道路）
";
CM_ SG_ 1019 AVN3FB_7_3_EYE_STOP_CSTM "特殊標識表示ON/OFF設定（一時停止）
";
CM_ SG_ 1019 AVN3FB_7_4_EYE_NO_ENTRY_CSTM "特殊標識表示ON/OFF設定（進入禁止）
";
CM_ SG_ 1019 AVN3FB_7_5_MVS_CAMERA_SELECT_SW "MVSｶﾒﾗ切替画面内ｽｲｯﾁ情報
";
CM_ SG_ 1019 AVN3FB_7_7_ACPANEL_DR_ONLY "ｴｱｺﾝﾊﾟﾈﾙ 一席集中 SW
";
CM_ SG_ 1019 AVN3FB_6_0_ACPANEL_PA_TEMP "ｴｱｺﾝﾊﾟﾈﾙ Ｐ席TEMP
";
CM_ SG_ 1019 AVN3FB_6_6_ACPANEL_MODE_DOWN "ｴｱｺﾝﾊﾟﾈﾙ 吹き出し口MODE- SW
";
CM_ SG_ 1019 AVN3FB_6_7_ACPANEL_MODE_UP "ｴｱｺﾝﾊﾟﾈﾙ 吹き出し口MODE+ SW
";
CM_ SG_ 1019 AVN3FB_5_0_ACPANEL_DR_TEMP "ｴｱｺﾝﾊﾟﾈﾙ D席TEMP
";
CM_ SG_ 1019 AVN3FB_5_6_ACPANEL_FAN_DOWN "ｴｱｺﾝﾊﾟﾈﾙ FAN DOWN SW
";
CM_ SG_ 1019 AVN3FB_5_7_ACPANEL_FAN_UP "ｴｱｺﾝﾊﾟﾈﾙ FAN UP SW
";
CM_ SG_ 1019 AVN3FB_4_0_ACPANEL_FAN_LEVEL "ｴｱｺﾝﾊﾟﾈﾙ FAN段数
";
CM_ SG_ 1019 AVN3FB_4_4_ACPANEL_MODE_VENT "ｴｱｺﾝﾊﾟﾈﾙ 吹き出し口MODE指定
";
CM_ SG_ 1019 AVN3FB_3_0_ACPANEL_PA_TEMP_DOWN "ｴｱｺﾝﾊﾟﾈﾙ P席TEMP設定DOWN SW
";
CM_ SG_ 1019 AVN3FB_3_1_ACPANEL_PA_TEMP_UP "ｴｱｺﾝﾊﾟﾈﾙ P席TEMP設定UP SW
";
CM_ SG_ 1019 AVN3FB_3_2_ACPANEL_DR_TEMP_DOWN "ｴｱｺﾝﾊﾟﾈﾙ D席TEMP設定DOWN SW
";
CM_ SG_ 1019 AVN3FB_3_3_ACPANEL_DR_TEMP_UP "ｴｱｺﾝﾊﾟﾈﾙ D席TEMP設定UP SW
";
CM_ SG_ 1019 AVN3FB_3_4_ACPANEL_SYNC "ｴｱｺﾝﾊﾟﾈﾙ SYNC SW
";
CM_ SG_ 1019 AVN3FB_3_5_ACPANEL_AC "ｴｱｺﾝﾊﾟﾈﾙ A/C SW
";
CM_ SG_ 1019 AVN3FB_3_6_F_DEF_SW "Front DEF SW
";
CM_ SG_ 1019 AVN3FB_3_7_R_DEF_SW "Rear DEF SW
";
CM_ SG_ 1019 AVN3FB_2_0_ACPANEL_AUTO "ｴｱｺﾝﾊﾟﾈﾙ AUTO SW
";
CM_ SG_ 1019 AVN3FB_2_1_ACPANEL_MAX_AC "ｴｱｺﾝﾊﾟﾈﾙ MAX A/C SW
";
CM_ SG_ 1019 AVN3FB_2_2_ACPANEL_SEAT_C_P "ｴｱｺﾝﾊﾟﾈﾙ ﾍﾞﾝﾁﾚｰｼｮﾝｼｰﾄ P席 SW
";
CM_ SG_ 1019 AVN3FB_2_3_ACPANEL_SEAT_C_D "ｴｱｺﾝﾊﾟﾈﾙ ﾍﾞﾝﾁﾚｰｼｮﾝｼｰﾄ D席 SW
";
CM_ SG_ 1019 AVN3FB_2_4_ACPANEL_SEAT_H_P "ｴｱｺﾝﾊﾟﾈﾙ SEAT HEATER P席 SW
";
CM_ SG_ 1019 AVN3FB_2_5_ACPANEL_SEAT_H_D "ｴｱｺﾝﾊﾟﾈﾙ SEAT HEATER D席 SW
";
CM_ SG_ 1019 AVN3FB_2_6_ACPANEL_INNER_AIR "ｴｱｺﾝﾊﾟﾈﾙ 内外気 SW
";
CM_ SG_ 1019 AVN3FB_2_7_ACPANEL_AC_ON_OFF "ｴｱｺﾝﾊﾟﾈﾙ 空調ON/OFF
";
CM_ SG_ 1019 AVN3FB_1_0_MSG_COUNTER "ﾒｯｾｰｼﾞｶｳﾝﾀ
";
CM_ SG_ 1019 AVN3FB_1_4_EYE_CSTM_REQ_3FB "EyeSightｶｽﾀﾏｲｽﾞ変更要求_3FB
";
CM_ SG_ 1019 AVN3FB_1_5_DDAW_WARNING_CSTM "DDAW ON/OFF設定
";
CM_ SG_ 1019 AVN3FB_1_6_SIGN_SWITCH_SND "標識切り替わり音 ON/OFF設定
";
CM_ SG_ 1019 AVN3FB_1_7_SLWF_CSTM "SLWF ON/OFF設定
";
CM_ SG_ 1019 AVN3FB_0_0_CHECK_SUM "ﾁｪｯｸｻﾑ
";
CM_ SG_ 1767 RES6E7_2_0_DATA2 "通信データ2
";
CM_ SG_ 1767 RES6E7_1_0_MSG_COUNTER "ﾒｯｾｰｼﾞｶｳﾝﾀ
";
CM_ SG_ 1767 RES6E7_1_4_DATA1 "通信データ1
";
CM_ SG_ 1767 RES6E7_0_0_CHECK_SUM "ﾁｪｯｸｻﾑ
";
CM_ SG_ 1765 RES6E5_6_0_REQ_DOOR_LOCK_ARM "再ARM用ﾄﾞｱﾛｯｸ要求
";
CM_ SG_ 1765 RES6E5_6_1_REQ_ST_ON "ST ON要求
";
CM_ SG_ 1765 RES6E5_6_2_REQ_POWER_ON "電源ON要求
";
CM_ SG_ 1765 RES6E5_6_3_ON_SIGN "ﾘﾓｽﾀON信号
";
CM_ SG_ 1765 RES6E5_5_5_REQ_PARKLIGHT_HORN "ﾊﾟｰｸﾗｲﾄ＆ﾎｰﾝ要求
";
CM_ SG_ 1765 RES6E5_1_0_MSG_COUNTER "ﾒｯｾｰｼﾞｶｳﾝﾀ
";
CM_ SG_ 1765 RES6E5_1_4_WAKE_UP_FRAME "ｳｪｲｸｱｯﾌﾟﾌﾚｰﾑ識別ﾌﾗｸﾞ
";
CM_ SG_ 1765 RES6E5_1_5_REQ_COMM_CONT "通信継続要求ﾌﾗｸﾞ
";
CM_ SG_ 1765 RES6E5_1_6 "予約:通信継続要求ﾌﾗｸﾞ(拡張)
";
CM_ SG_ 1765 RES6E5_0_0_CHECK_SUM "ﾁｪｯｸｻﾑ
";
CM_ SG_ 1635 AHL663_3_0_FAIL_ADB "ADB故障警告灯
";
CM_ SG_ 1635 AHL663_3_2_HEADLAMP_HI_IND "ﾍｯﾄﾞﾗﾝﾌﾟ Hiﾋﾞｰﾑｲﾝｼﾞｹｰﾀ
";
CM_ SG_ 1635 AHL663_3_3_ADB_ACTIVE_IND "ADB作動ｲﾝｼﾞｹｰﾀ
";
CM_ SG_ 1635 AHL663_3_4_CSTM_SRH_OFF "SRH OFF 機能ｶｽﾀﾏｲｽﾞ設定
";
CM_ SG_ 1635 AHL663_2_0_FAIL_AHL "ｵｰﾄﾍｯﾄﾞﾗﾝﾌﾟﾚﾍﾞﾗ異常
";
CM_ SG_ 1635 AHL663_2_3_FAIL_LED_HEADLAMP "LEDﾍｯﾄﾞﾗﾝﾌﾟ異常
";
CM_ SG_ 1635 AHL663_2_5_IND_AFS "AFSｲﾝｼﾞｹｰﾀ信号
";
CM_ SG_ 1635 AHL663_1_0_MSG_COUNTER "ﾒｯｾｰｼﾞｶｳﾝﾀ
";
CM_ SG_ 1635 AHL663_1_6 "予約:通信継続要求ﾌﾗｸﾞ(拡張)
";
CM_ SG_ 1635 AHL663_0_0_CHECK_SUM "ﾁｪｯｸｻﾑ
";
CM_ SG_ 985 AHL3D9_3_0_ROLL_ANGLE "ロール角
";
CM_ SG_ 985 AHL3D9_2_0_PITCH_ANGLE "ピッチ角
";
CM_ SG_ 985 AHL3D9_1_0_MSG_COUNTER "ﾒｯｾｰｼﾞｶｳﾝﾀ
";
CM_ SG_ 985 AHL3D9_1_4_AHL_STATE "AHL状態
";
CM_ SG_ 985 AHL3D9_0_0_CHECK_SUM "チェックサム
";
CM_ SG_ 1363 AHL553_7_0_NETWORK_STATUS "ﾈｯﾄﾜｰｸｽﾃｰﾀｽ
";
CM_ SG_ 1631 IMB65F_2_0_DATA2 "照合データ2
";
CM_ SG_ 1631 IMB65F_1_0_MSG_COUNTER "ﾒｯｾｰｼﾞｶｳﾝﾀ
";
CM_ SG_ 1631 IMB65F_1_4_DATA1 "照合データ1
";
CM_ SG_ 1631 IMB65F_0_0_CHECK_SUM "ﾁｪｯｸｻﾑ
";
CM_ SG_ 1296 PSM510_1_4_ActiveWakeUpBit "Active Wakeup ﾌﾗｸﾞ
";
CM_ SG_ 1296 PSM510_0_0_SourceNodeID "送信元ID
";
CM_ SG_ 1639 PSC667_3_0_SEAT_SW_ANOMALOUS "シートスイッチ異常
";
CM_ SG_ 1639 PSC667_3_1_SEAT_MOT_ANOMALOUS "シートモータ故障
";
CM_ SG_ 1639 PSC667_3_2_SEAT_PLS_ANOMALOUS "シートパルス故障
";
CM_ SG_ 1639 PSC667_2_0_NVM_ANOMALOUS "不揮発性メモリ異常
";
CM_ SG_ 1639 PSC667_2_1_POWER_ANOMALOUS "電源電圧異常
";
CM_ SG_ 1639 PSC667_1_0_MSG_COUNTER "メッセージカウンタ
";
CM_ SG_ 1639 PSC667_0_0_CHECK_SUM "チェックサム
";
CM_ SG_ 1638 PSC666_3_0_PSC_APPLY_CONST "PSC：　適用定数
";
CM_ SG_ 1638 PSC666_2_0_MNL_SW_TLT_SEAT "シート：　マニュアルSW　TLT
";
CM_ SG_ 1638 PSC666_2_2_MNL_SW_LFT_SEAT "シート：　マニュアルSW　LFT
";
CM_ SG_ 1638 PSC666_2_4_MNL_SW_RCL_SEAT "シート：　マニュアルSW　RCL
";
CM_ SG_ 1638 PSC666_2_6_MNL_SW_SLD_SEAT "シート：　マニュアルSW　SLD
";
CM_ SG_ 1638 PSC666_1_0_MSG_COUNTER "メッセージカウンタ
";
CM_ SG_ 1638 PSC666_0_0_CHECK_SUM "チェックサム
";
CM_ SG_ 1624 PSC658_7_0_CUR_POS_TLT "シート：　現在位置　TLT
";
CM_ SG_ 1624 PSC658_5_2_STATE_ACT_TLT "シート：　作動状態　TLT
";
CM_ SG_ 1624 PSC658_5_4_FACTOR_ACT_TLT "シート：　作動要因　TLT
";
CM_ SG_ 1624 PSC658_4_0_CUR_POS_LFT "シート：　現在位置　LFT
";
CM_ SG_ 1624 PSC658_2_2_STATE_ACT_LFT "シート：　作動状態　LFT
";
CM_ SG_ 1624 PSC658_2_4_FACTOR_ACT_LFT "シート：　作動要因　LFT
";
CM_ SG_ 1624 PSC658_1_0_MSG_COUNTER "メッセージカウンタ
";
CM_ SG_ 1624 PSC658_0_0_CHECK_SUM "チェックサム
";
CM_ SG_ 1623 PSC657_7_0_CUR_POS_RCL "シート：　現在位置　RCL
";
CM_ SG_ 1623 PSC657_5_2_STATE_ACT_RCL "シート：　作動状態　RCL
";
CM_ SG_ 1623 PSC657_5_4_FACTOR_ACT_RCL "シート：　作動要因　RCL
";
CM_ SG_ 1623 PSC657_4_0_CUR_POS_SLD "シート：　現在位置　SLD
";
CM_ SG_ 1623 PSC657_2_2_STATE_ACT_SLD "シート：　作動状態　SLD
";
CM_ SG_ 1623 PSC657_2_4_FACTOR_ACT_SLD "シート：　作動要因　SLD
";
CM_ SG_ 1623 PSC657_1_0_MSG_COUNTER "メッセージカウンタ
";
CM_ SG_ 1623 PSC657_0_0_CHECK_SUM "チェックサム
";
CM_ SG_ 1298 MEP512_1_4_ActiveWakeUpBit "Active Wakeup ﾌﾗｸﾞ
";
CM_ SG_ 1298 MEP512_0_0_SourceNodeID "送信元ID
";
CM_ SG_ 1297 MED511_1_4_ActiveWakeUpBit "Active Wakeup ﾌﾗｸﾞ
";
CM_ SG_ 1297 MED511_0_0_SourceNodeID "送信元ID
";
CM_ SG_ 1645 PRG66D_4_0_BUZZER_RQ_PRG "PRGﾌﾞｻﾞｰ吹鳴要求
";
CM_ SG_ 1645 PRG66D_4_7_PRG_HF_ON_OFF "PRGハンズフリーON/OFF状態
";
CM_ SG_ 1645 PRG66D_3_1_PRG_MEMORY_ON_OFF "PRGﾒﾓﾘ機能　ON/OFF状態
";
CM_ SG_ 1645 PRG66D_3_3_PRG_LOCK_SW_RQ "PRGﾛｯｸSW作動要求
";
CM_ SG_ 1645 PRG66D_3_5_KICK_CSTM_TIMER "ｷｯｸｾﾝｻｶｽﾀﾏｲｽﾞ時間
";
CM_ SG_ 1645 PRG66D_2_2_HAZARD "ハザード信号
";
CM_ SG_ 1645 PRG66D_1_0_MSG_COUNTER "ﾒｯｾｰｼﾞｶｳﾝﾀ
";
CM_ SG_ 1645 PRG66D_0_0_CHECK_SUM "ﾁｪｯｸｻﾑ
";
CM_ SG_ 1294 PRG50E_1_4_ActiveWakeUpBit "Active Wakeup ﾌﾗｸﾞ
";
CM_ SG_ 1294 PRG50E_0_0_SourceNodeID "送信元ID
";
CM_ SG_ 1646 PRG66E_7_0_FACT_PRG_REFUSE_FAIL "PRG作動拒否要因（故障）
";
CM_ SG_ 1646 PRG66E_6_0_FACT_PRG_REFUSE "PRG作動拒否要因（故障除く）
";
CM_ SG_ 1646 PRG66E_5_5_PERMIT_PRG_OPER "PRG作動可否
";
CM_ SG_ 1646 PRG66E_4_0_PERM_PRG_OPER_OPEN "PRG閉作動可否
";
CM_ SG_ 1646 PRG66E_4_1_PERM_PRG_OPER_OPEN "PRG開作動可否
";
CM_ SG_ 1646 PRG66E_4_2_FACT_PRG_OPER "PRG作動要因
";
CM_ SG_ 1646 PRG66E_4_6_CUR_RG_STATE "リヤゲート現在位置
";
CM_ SG_ 1646 PRG66E_3_0_CUR_POS_RG "リヤゲート全閉からの位置
";
CM_ SG_ 1646 PRG66E_2_4_SW_PRG_PULS_CLOSE "PRGプルスタート作動　閉方向
";
CM_ SG_ 1646 PRG66E_2_5_SW_PRG_PULS_OPEN "PRGプルスタート作動　開方向
";
CM_ SG_ 1646 PRG66E_2_6_SW_PRG_LOCK "PRGロックSW ON/OFF
";
CM_ SG_ 1646 PRG66E_2_7_SW_PRG_INNER "PRGインナーSW ON/OFF
";
CM_ SG_ 1646 PRG66E_1_0_MSG_COUNTER "メッセージカウンタ
";
CM_ SG_ 1646 PRG66E_1_4_STATUS_PRG_OPER "PRG作動状態
";
CM_ SG_ 1646 PRG66E_1_7_PERMIT_MEM_POS_PRG "PRGメモリー位置登録　許可状態
";
CM_ SG_ 1646 PRG66E_0_0_CHECK_SUM "チェックサム
";
CM_ SG_ 1628 PRG65C_3_0_FLAG_PRG_FAIL_B "PRG異常フラグB
";
CM_ SG_ 1628 PRG65C_2_0_FLAG_PRG_FAIL_A "PRG異常フラグA
";
CM_ SG_ 1628 PRG65C_1_0_MSG_COUNTER "メッセージカウンタ
";
CM_ SG_ 1628 PRG65C_0_0_CHECK_SUM "チェックサム
";
CM_ SG_ 818 PMN332_7_0_RES_CONTROL_STATUS "リモスタ制御状態
";
CM_ SG_ 818 PMN332_7_2_REQ_RES_P_LOCK "ﾘﾓｽﾀ制御ｼﾌﾄPﾛｯｸ要求
";
CM_ SG_ 818 PMN332_7_5_IGB_RELAY_REQ "IGbリレー指示値
";
CM_ SG_ 818 PMN332_7_6_IGA_RELAY_REQ "IGaリレー指示値
";
CM_ SG_ 818 PMN332_7_7_REQ_STOP_RES "ﾘﾓｽﾀ停止要求
";
CM_ SG_ 818 PMN332_6_0_RES_IDLE_TIME "ﾘﾓｽﾀ累積ｴﾝｼﾞﾝON時間
";
CM_ SG_ 818 PMN332_6_7_CUST "自動E/G停止カスタマイズ設定値
";
CM_ SG_ 818 PMN332_5_0_PUSHSTART_SW "ﾌﾟｯｼｭｽﾀｰﾄSW信号
";
CM_ SG_ 818 PMN332_5_1_SIG_KEY_PUSHSTART "ﾌﾟｯｼｭｽﾀｰﾄ用ｷｰ信号
";
CM_ SG_ 818 PMN332_5_2_STATE_MODE_POWER "電源ﾓｰﾄﾞ状態信号
";
CM_ SG_ 818 PMN332_5_4_BUZ_2SHOT_IN "室内ﾌﾞｻﾞｰ　単発2回吹鳴要求
";
CM_ SG_ 818 PMN332_5_5_BUZ_INTERMIT1_IN "室内ﾌﾞｻﾞｰ　断続吹鳴1要求
";
CM_ SG_ 818 PMN332_5_6_BUZ_INTERMIT2_IN "室内ﾌﾞｻﾞｰ　断続吹鳴2要求(0.7s周期)
";
CM_ SG_ 818 PMN332_5_7_BUZ_CONTINUE_IN "室内ﾌﾞｻﾞｰ　連続吹鳴要求
";
CM_ SG_ 818 PMN332_2_0_WARN_SSP_SIG1 "ｽﾏｰﾄｼｽﾃﾑ警報信号(電源)1
";
CM_ SG_ 818 PMN332_2_1_WARN_SSP_SIG2 "ｽﾏｰﾄｼｽﾃﾑ警報信号(電源)2
";
CM_ SG_ 818 PMN332_2_4_SMT_PWR_SIG "ｽﾏｰﾄｼｽﾃﾑ電源状態信号
";
CM_ SG_ 818 PMN332_2_7_BUZ_1SHOT_IN "室内ﾌﾞｻﾞｰ　単発1回吹鳴
";
CM_ SG_ 818 PMN332_1_0_MSG_COUNTER "ﾒｯｾｰｼﾞｶｳﾝﾀ
";
CM_ SG_ 818 PMN332_0_0_CHECK_SUM "ﾁｪｯｸｻﾑ
";
CM_ SG_ 1303 PMN517_1_4_ActiveWakeUpBit "Active Wakeup ﾌﾗｸﾞ
";
CM_ SG_ 1303 PMN517_0_0_SourceNodeID "送信元ID
";
CM_ SG_ 1603 SMT643_2_0_DATA2 "通信データ2
";
CM_ SG_ 1603 SMT643_1_0_MSG_COUNTER "ﾒｯｾｰｼﾞｶｳﾝﾀ
";
CM_ SG_ 1603 SMT643_1_4_DATA1 "通信データ1
";
CM_ SG_ 1603 SMT643_0_0_CHECK_SUM "ﾁｪｯｸｻﾑ
";
CM_ SG_ 1601 SMT641_5_0_RKE_BODY_INF_BYTE3 "RKE-BODY間通信INF-Byte3
";
CM_ SG_ 1601 SMT641_4_0_RKE_BODY_INF_BYTE2 "RKE-BODY間通信INF-Byte2
";
CM_ SG_ 1601 SMT641_3_0_RKE_BODY_INF_BYTE1 "RKE-BODY間通信INF-Byte1
";
CM_ SG_ 1601 SMT641_2_0_RKE_BODY_CTL_BYTE "RKE-BODY間通信CTL-Byte
";
CM_ SG_ 1601 SMT641_1_0_MSG_COUNTER "ﾒｯｾｰｼﾞｶｳﾝﾀ
";
CM_ SG_ 1601 SMT641_0_0_CHECK_SUM "ﾁｪｯｸｻﾑ
";
CM_ SG_ 1600 SMT640_7_0_RES_CONTROL_STATUS "リモスタ制御状態
";
CM_ SG_ 1600 SMT640_7_2_REQ_RES_P_LOCK "ﾘﾓｽﾀ制御ｼﾌﾄPﾛｯｸ要求
";
CM_ SG_ 1600 SMT640_7_4_KEY_STATUS "キー状態
";
CM_ SG_ 1600 SMT640_7_5_KEY_SEARCH_RESULT "車室内ｱｸｾｽｷｰ判定結果
";
CM_ SG_ 1600 SMT640_7_7_REQ_STOP_RES "ﾘﾓｽﾀ停止要求
";
CM_ SG_ 1600 SMT640_6_0_RES_IDLE_TIME "ﾘﾓｽﾀ累積ｴﾝｼﾞﾝON時間
";
CM_ SG_ 1600 SMT640_5_1_IND_SECURITY "ｾｷｭﾘﾃｨｲﾝｼﾞｹｰﾀ駆動
";
CM_ SG_ 1600 SMT640_5_3_BUZ_WAL_WIUL_PAUSE "WAL/WIUL一時停止モード設定ブザー吹鳴要求
";
CM_ SG_ 1600 SMT640_5_4_BUZ_ALA_MAX "室外ブザー警笛MAX音量
";
CM_ SG_ 1600 SMT640_5_5_PRG_LOCK_SW_STATE "PRGロックSW状態信号
";
CM_ SG_ 1600 SMT640_3_0_VERIFY_VALUE_OUT "車室外照合結果信号
";
CM_ SG_ 1600 SMT640_2_0_BUZ_NUM_OUT "室外ﾌﾞｻﾞｰ吹鳴回数
";
CM_ SG_ 1600 SMT640_2_4_BUZ_PAT_OUT "室外ﾌﾞｻﾞｰ吹鳴ﾊﾟﾀｰﾝ
";
CM_ SG_ 1600 SMT640_1_0_MSG_COUNTER "ﾒｯｾｰｼﾞｶｳﾝﾀ
";
CM_ SG_ 1600 SMT640_0_0_CHECK_SUM "ﾁｪｯｸｻﾑ
";
CM_ SG_ 816 SMT330_7_0 "プッシュSW故障
";
CM_ SG_ 816 SMT330_7_1 "IG OFF予告
";
CM_ SG_ 816 SMT330_7_3_HF_CAPA_ERR_ST "HFｾﾝｻｰ静電容量異常状態
";
CM_ SG_ 816 SMT330_7_6_HF_RESP_ERR_ST "HFｾﾝｻｰﾚｽﾎﾟﾝｽｴﾗｰ
";
CM_ SG_ 816 SMT330_6_0_REQ_MESS_PUSHSTART "ﾌﾟｯｼｭｽﾀｰﾄﾒｯｾｰｼﾞ要求
";
CM_ SG_ 816 SMT330_6_4_WARN_SSP_SIG1 "ｽﾏｰﾄｼｽﾃﾑ警報信号1
";
CM_ SG_ 816 SMT330_5_1_WIUL_CUST "WIUL機能ｶｽﾀﾏｲｽﾞ
";
CM_ SG_ 816 SMT330_5_2_WAL_CUST "WAL機能ｶｽﾀﾏｲｽﾞ
";
CM_ SG_ 816 SMT330_5_3_WARN_SSP_SIG2 "ｽﾏｰﾄｼｽﾃﾑ警報信号2
";
CM_ SG_ 816 SMT330_5_5_WARN_SSP_SIG3 "ｽﾏｰﾄｼｽﾃﾑ警報信号3
";
CM_ SG_ 816 SMT330_4_0_PUSHSTART_SW "ﾌﾟｯｼｭｽﾀｰﾄSW信号
";
CM_ SG_ 816 SMT330_4_1_SIG_KEY_PUSHSTART "ﾌﾟｯｼｭｽﾀｰﾄ用ｷｰ信号
";
CM_ SG_ 816 SMT330_4_2_HF_TOUCH_STATUS "HFｾﾝｻｰ検出状態
";
CM_ SG_ 816 SMT330_4_5_HF_KICK_STATUS "ｷｯｸｾﾝｻｰ検出状態
";
CM_ SG_ 816 SMT330_3_0_BUZ_1SHOT_IN "室内ﾌﾞｻﾞｰ　単発1回吹鳴要求
";
CM_ SG_ 816 SMT330_3_1_BUZ_2SHOT_IN "室内ﾌﾞｻﾞｰ　単発2回吹鳴要求
";
CM_ SG_ 816 SMT330_3_2_BUZ_INTERMIT1_IN "室内ﾌﾞｻﾞｰ　断続吹鳴1要求
";
CM_ SG_ 816 SMT330_3_3_BUZ_INTERMIT2_IN "室内ﾌﾞｻﾞｰ　断続吹鳴2要求（0.7s周期）
";
CM_ SG_ 816 SMT330_3_4_BUZ_CONTINUE_IN "室内ﾌﾞｻﾞｰ　連続吹鳴要求
";
CM_ SG_ 816 SMT330_3_5_BUZ_TRPON_OK_IN "室内ﾌﾞｻﾞｰ　ﾄﾗﾎﾟﾝ照合完了通知要求
";
CM_ SG_ 816 SMT330_3_6_STATE_MODE_POWER "電源ﾓｰﾄﾞ状態信号
";
CM_ SG_ 816 SMT330_1_0_MSG_COUNTER "ﾒｯｾｰｼﾞｶｳﾝﾀ
";
CM_ SG_ 816 SMT330_1_4_WAKE_UP_FRAME "ｳｪｲｸｱｯﾌﾟﾌﾚｰﾑ識別ﾌﾗｸﾞ
";
CM_ SG_ 816 SMT330_1_5_REQ_COMM_CONT "通信継続要求ﾌﾗｸﾞ
";
CM_ SG_ 816 SMT330_1_6 "予約:通信継続要求ﾌﾗｸﾞ(拡張)
";
CM_ SG_ 816 SMT330_0_0_CHECK_SUM "ﾁｪｯｸｻﾑ
";
CM_ SG_ 1289 SMT509_1_4_ActiveWakeUpBit "Active Wakeup ﾌﾗｸﾞ
";
CM_ SG_ 1289 SMT509_0_0_SourceNodeID "送信元ID
";
CM_ SG_ 1759 BIU6DF_2_1_ALARM_DATA "ｱﾗｰﾑ状態
";
CM_ SG_ 1759 BIU6DF_1_1_DATA "ｲﾓﾋﾞ状態
";
CM_ SG_ 1622 BIU656_6_0_KICK_OPEN_REQ_PRG "ｷｯｸ要因PRGｵｰﾌﾟﾝ要求
";
CM_ SG_ 1622 BIU656_6_1_KICK_CLOSE_REQ_PRG "ｷｯｸ要因PRGｸﾛｰｽﾞ要求
";
CM_ SG_ 1622 BIU656_6_6_CARGO_LAMP_OUT "カーゴランプ出力情報
";
CM_ SG_ 1622 BIU656_6_7_PERMITT_KEY_RG_UNL "キーレス R/G SW RG解錠許可状態
";
CM_ SG_ 1622 BIU656_5_0_PRG_DRVR_OPENERSW "PRGD席ｵｰﾌﾟﾅSW
";
CM_ SG_ 1622 BIU656_5_1_HF_PRG_OFF_SW "ﾊﾝｽﾞﾌﾘｰPRG OFF SW
";
CM_ SG_ 1622 BIU656_5_2_PERMIT_OPEN_RG "R/Gｵｰﾌﾟﾝ許可状態
";
CM_ SG_ 1622 BIU656_5_3_BUZ_ON_OFF "ﾌﾞｻﾞｰ吹鳴ON/OFF
";
CM_ SG_ 1622 BIU656_5_4_PRG_DRVR_SW_PERMIT "PRG D席ｵｰﾌﾟﾅｰSW許可状態
";
CM_ SG_ 1622 BIU656_5_5_CSTM_HF_PRG_LOCK "ﾊﾝｽﾞﾌﾘｰPRGﾛｯｸ有無
";
CM_ SG_ 1622 BIU656_5_6_CSTM_KICK_SENSOR "ｷｯｸｾﾝｻ有無
";
CM_ SG_ 1622 BIU656_5_7_KICK_REQ_PRG "ｷｯｸ要因PRG駆動要求
";
CM_ SG_ 1622 BIU656_4_0_NOT_SMT_KEY_RG_SW "ｷｰﾚｽ R/G SW（ｽﾏｰﾄ無し車）
";
CM_ SG_ 1622 BIU656_4_2_SMT_KEY_RG_SW "ｷｰﾚｽ R/G SW（ｽﾏｰﾄ有り車）
";
CM_ SG_ 1622 BIU656_4_4_OPEN_RG_OPENER_SW "RｹﾞｰﾄｵｰﾌﾟﾅSW駆動処理
";
CM_ SG_ 1622 BIU656_3_4_CHECKED_KEYNO "照合ｷｰNo.
";
CM_ SG_ 1622 BIU656_3_7_LOCKSTATUS_DRVR "ﾄﾞｱﾛｯｸ状態信号（運席）
";
CM_ SG_ 1622 BIU656_2_0_TRIG_LOCK_UNLOCK "ﾄﾞｱﾛｯｸ/ｱﾝﾛｯｸ出力情報
";
CM_ SG_ 1622 BIU656_1_0_MSG_COUNTER "ﾒｯｾｰｼﾞｶｳﾝﾀ
";
CM_ SG_ 1622 BIU656_0_0_CHECK_SUM "ﾁｪｯｸｻﾑ
";
CM_ SG_ 1621 BIU655_4_0_BUZZER_PATTERN "ﾌﾞｻﾞｰ出力ﾊﾟﾀｰﾝ要求
";
CM_ SG_ 1621 BIU655_3_0_BUZZER_VOL_REQ "室外ﾌﾞｻﾞｰ音量要求
";
CM_ SG_ 1621 BIU655_3_3_RDEF_RELAY_REQ "ﾘｱﾃﾞﾌｫｯｶﾞ出力要求
";
CM_ SG_ 1621 BIU655_3_4_WIPER_DEICER_REQ "ﾜｲﾊﾟﾃﾞｱｲｻ出力要求
";
CM_ SG_ 1621 BIU655_3_5_FT_WIPER_REQ "Fﾜｲﾊﾟ駆動要求
";
CM_ SG_ 1621 BIU655_2_0_RR_WIPER_REQ "Rﾜｲﾊﾟ駆動要求
";
CM_ SG_ 1621 BIU655_2_1_WASHER_REQ "ｳｫｯｼｬ出力要求
";
CM_ SG_ 1621 BIU655_2_3_HL_WASHER_REQ "H/Lｳｫｯｼｬ出力要求
";
CM_ SG_ 1621 BIU655_2_4_FT_FOG_RELAY_REQ "Fﾌｫｸﾞﾗﾝﾌﾟﾘﾚｰ出力要求
";
CM_ SG_ 1621 BIU655_2_5_HEADLAMP_HI_REQ "ﾗｲﾃｨﾝｸﾞHi出力要求
";
CM_ SG_ 1621 BIU655_2_7_HEADLAMP_LO_REQ "ﾗｲﾃｨﾝｸﾞLo出力要求
";
CM_ SG_ 1621 BIU655_1_0_MSG_COUNTER "ﾒｯｾｰｼﾞｶｳﾝﾀ
";
CM_ SG_ 1621 BIU655_0_0_CHECK_SUM "ﾁｪｯｸｻﾑ
";
CM_ SG_ 1620 BIU654_7_4_KEYSW "ｷｰSW
";
CM_ SG_ 1620 BIU654_7_5_ALARM "ｱﾗｰﾑｼｽﾃﾑ情報
";
CM_ SG_ 1620 BIU654_7_6_RES_STOP_JPN "ｴﾝｽﾀ停止要求
";
CM_ SG_ 1620 BIU654_6_0_CONT_DATA_FOR_RES "RES用ｺﾏﾝﾄﾞ
";
CM_ SG_ 1620 BIU654_2_0_CODE_IMB_FOR_RES "Iﾃﾞｰﾀ
";
CM_ SG_ 1620 BIU654_1_0_MSG_COUNTER "ﾒｯｾｰｼﾞｶｳﾝﾀ
";
CM_ SG_ 1620 BIU654_0_0_CHECK_SUM "ﾁｪｯｸｻﾑ
";
CM_ SG_ 1618 BIU652_7_0_IND_SECURITY_IMB "ｾｷｭﾘﾃｨ(ｲﾓﾋﾞ)ｲﾝｼﾞｹｰﾀ表示
";
CM_ SG_ 1618 BIU652_6_0_OCCUPATION_3RDRH "3列目右乗員有無信号
";
CM_ SG_ 1618 BIU652_6_1_OCCUPATION_3RDCTR "3列目中央乗員有無信号
";
CM_ SG_ 1618 BIU652_6_2_OCCUPATION_3RDLH "3列目左乗員有無信号
";
CM_ SG_ 1618 BIU652_6_3_OCCUPATION_RRRH "後席右乗員有無信号
";
CM_ SG_ 1618 BIU652_6_4_OCCUPATION_RRCTR "後席中央乗員有無信号
";
CM_ SG_ 1618 BIU652_6_5_OCCUPATION_RRLH "後席左乗員有無信号
";
CM_ SG_ 1618 BIU652_6_6_HORNHAZARD_RES_SIG "ﾘﾓｰﾄﾎｰﾝ&ﾗｲﾄ応答信号
";
CM_ SG_ 1618 BIU652_6_7_OCCUPATION_DRVR "D席乗員有無信号
";
CM_ SG_ 1618 BIU652_5_0_STATUS_ROOMLAMP "ﾙｰﾑﾗﾝﾌﾟ状態
";
CM_ SG_ 1618 BIU652_5_3_HEADLAMP_SMALL "ﾍｯﾄﾞﾗﾝﾌﾟ　ｽﾓｰﾙ
";
CM_ SG_ 1618 BIU652_5_4_ALL_UNLOCK_STATE "全席ｱﾝﾛｯｸ出力状態
";
CM_ SG_ 1618 BIU652_5_5_DRVR_UNLOCK_STATE "運転席ｱﾝﾛｯｸ出力状態
";
CM_ SG_ 1618 BIU652_5_6_ALL_LOCK_STATE "全席ﾛｯｸ出力状態
";
CM_ SG_ 1618 BIU652_4_0_TRIG_LOCK_UNLOCK "ﾄﾞｱﾛｯｸ/ｱﾝﾛｯｸ出力要因信号
";
CM_ SG_ 1618 BIU652_3_0_DOOR_DRVR "ﾄﾞｱSW　D席
";
CM_ SG_ 1618 BIU652_3_1_DOOR_PASS "ﾄﾞｱSW　P席
";
CM_ SG_ 1618 BIU652_3_2_DOOR_RRRH "ﾄﾞｱSW　後席右
";
CM_ SG_ 1618 BIU652_3_3_DOOR_RRLH "ﾄﾞｱSW　後席左
";
CM_ SG_ 1618 BIU652_3_4_DOOR_RG "ﾄﾞｱSW　Rｹﾞｰﾄ
";
CM_ SG_ 1618 BIU652_3_5_DOOR_TR "ﾄﾞｱSW　ﾄﾗﾝｸ
";
CM_ SG_ 1618 BIU652_3_7_OPENSW_RG "ﾘﾔｹﾞｰﾄｵｰﾌﾟﾅSW信号
";
CM_ SG_ 1618 BIU652_2_0_LOCKSTATUS_DRVR "ﾄﾞｱﾛｯｸ状態信号（運席）
";
CM_ SG_ 1618 BIU652_2_1_LOCKSTATUS_PASS "ﾄﾞｱﾛｯｸ状態信号（助手席）
";
CM_ SG_ 1618 BIU652_2_2_LOCKSTATUS_RRRH "ﾄﾞｱﾛｯｸ状態信号（後席右）
";
CM_ SG_ 1618 BIU652_2_3_LOCKSTATUS_RRLH "ﾄﾞｱﾛｯｸ状態信号（後席左）
";
CM_ SG_ 1618 BIU652_2_4_LOCKSTATUS_RG "ﾄﾞｱﾛｯｸ状態信号（Rｹﾞｰﾄ）
";
CM_ SG_ 1618 BIU652_2_6_UNLOCK_DOORKEYSW "ﾄﾞｱｷｰSW　ｱﾝﾛｯｸ
";
CM_ SG_ 1618 BIU652_2_7_LOCK_DOORKEYSW "ﾄﾞｱｷｰSW ﾛｯｸ
";
CM_ SG_ 1618 BIU652_1_0_MSG_COUNTER "ﾒｯｾｰｼﾞｶｳﾝﾀ
";
CM_ SG_ 1618 BIU652_0_0_CHECK_SUM "ﾁｪｯｸｻﾑ
";
CM_ SG_ 1617 BIU651_7_0_PWPOS_RL "RL席窓位置
";
CM_ SG_ 1617 BIU651_7_2_PWPOS_RR "RR席窓位置
";
CM_ SG_ 1617 BIU651_7_4_PWPOS_PASS "P席窓位置
";
CM_ SG_ 1617 BIU651_7_6_PWPOS_DRVR "D席窓位置
";
CM_ SG_ 1617 BIU651_6_0_IND_ACTIVE_HBA "HBA作動灯
";
CM_ SG_ 1617 BIU651_6_2_ADB_ACTIVE "ADB有無ﾌﾗｸﾞ
";
CM_ SG_ 1617 BIU651_6_3_JUDGE_ILL "照度判定信号
";
CM_ SG_ 1617 BIU651_6_4_TYPE_LO_BEAM "Loﾋﾞｰﾑ光源種類
";
CM_ SG_ 1617 BIU651_6_6_TYPE_HI_BEAM "Hiﾋﾞｰﾑ光源種類
";
CM_ SG_ 1617 BIU651_5_0_SRF_ACTIVE "SRF有無ﾌﾗｸﾞ
";
CM_ SG_ 1617 BIU651_5_1_SRF_IND "SRF OFF ｲﾝｼﾞｹｰﾀ
";
CM_ SG_ 1617 BIU651_5_3_SRF_LAMP_LIGHT "SRF（右）点灯状態
";
CM_ SG_ 1617 BIU651_5_4_SRF_LAMP_LEFT "SRF（左）点灯状態
";
CM_ SG_ 1617 BIU651_5_5_MSG_STATUS_HBA "HBA文言表示
";
CM_ SG_ 1617 BIU651_5_7_IND_FAIL_HBA "HBAﾌｪｰﾙ灯
";
CM_ SG_ 1617 BIU651_4_0_BUZ_PATTERN "ﾌﾞｻﾞｰ吹鳴ﾊﾟﾀｰﾝ情報
";
CM_ SG_ 1617 BIU651_4_4_CSTM_OPE_ALARM "ｾｷｭﾘﾃｨｱﾗｰﾑ　ｶｽﾀﾏｲｽﾞ
";
CM_ SG_ 1617 BIU651_4_6_CSTM_HBA "HBA（ﾐﾗｰ/ｱｲｻｲﾄ）有無ﾌﾗｸﾞ
";
CM_ SG_ 1617 BIU651_3_0_HEADLAMP_PASS_SW "ﾍｯﾄﾞﾗﾝﾌﾟ　PASSｽｲｯﾁ
";
CM_ SG_ 1617 BIU651_3_1_HEADLAMP_AUTO_SW "ﾍｯﾄﾞﾗﾝﾌﾟ　AUTOｽｲｯﾁ
";
CM_ SG_ 1617 BIU651_3_2_JUDGE_DOOR_LOCK "室内照明制御用ﾄﾞｱﾛｯｸ判定ﾌﾗｸﾞ
";
CM_ SG_ 1617 BIU651_3_3_JUDGE_DOOR_UNLOCK "室内照明制御用ﾄﾞｱｱﾝﾛｯｸ判定
";
CM_ SG_ 1617 BIU651_3_4_HEADLAMP_Lo_SW "ﾍｯﾄﾞﾗﾝﾌﾟ　Loｽｲｯﾁ
";
CM_ SG_ 1617 BIU651_3_5_HEADLAMP_HI_SW "ﾍｯﾄﾞﾗﾝﾌﾟ　Hiｽｲｯﾁ
";
CM_ SG_ 1617 BIU651_3_6_WIPER_AUTO_SW "ﾜｲﾊﾟｰ AUTO SW
";
CM_ SG_ 1617 BIU651_3_7_PRG_LIN_MEMORY_ON_OFF "PRG LIN通信用 メモリ機能 ON/OFF状態
";
CM_ SG_ 1617 BIU651_2_0_CSTM_ILLUMI_SSR "照度ｾﾝｻ有無ﾌﾗｸﾞ
";
CM_ SG_ 1617 BIU651_2_1_HANDLE "ﾊﾝﾄﾞﾙ情報
";
CM_ SG_ 1617 BIU651_2_2_CSTM_SMT "ｽﾏｰﾄ有無
";
CM_ SG_ 1617 BIU651_2_3_AJARDOOR_STATUS "半ﾄﾞｱ判定結果
";
CM_ SG_ 1617 BIU651_2_4_ONETOUCH_LAMP_OUT "ﾜﾝﾀｯﾁ全照明出力
";
CM_ SG_ 1617 BIU651_2_5_PRG_FAIL_FLAG "PRG通信異常フラグ
";
CM_ SG_ 1617 BIU651_2_6_CSTM_PSMECU "ｼｰﾄﾒﾓﾘ有無ﾌﾗｸﾞ
";
CM_ SG_ 1617 BIU651_2_7_STATE_REGIST_DEL "ﾒﾓﾘ登録/消去状態ﾌﾗｸﾞ
";
CM_ SG_ 1617 BIU651_1_0_MSG_COUNTER "ﾒｯｾｰｼﾞｶｳﾝﾀ
";
CM_ SG_ 1617 BIU651_1_4_SRPOS "サンルーフガラス位置
";
CM_ SG_ 1617 BIU651_1_7_WIPER_INT_STATUS "Fﾜｲﾊﾟ間欠作動状態
";
CM_ SG_ 1617 BIU651_0_0_CHECK_SUM "ﾁｪｯｸｻﾑ
";
CM_ SG_ 995 BIU3E3_7_2_FAIL_HUMID "湿度ｾﾝｻ故障
";
CM_ SG_ 995 BIU3E3_6_0_DATA_HUMID "湿度ｾﾝｻ
";
CM_ SG_ 995 BIU3E3_5_2_FAIL_HUMID_ATM_TMP "湿度(雰囲気温度)ｾﾝｻ故障
";
CM_ SG_ 995 BIU3E3_4_0_DATA_HUMID_ATM_TMP "湿度(雰囲気温度)ｾﾝｻ
";
CM_ SG_ 995 BIU3E3_3_2_FAIL_HUMID_GLA_TMP "湿度(窓ｶﾞﾗｽ温度)ｾﾝｻ故障
";
CM_ SG_ 995 BIU3E3_3_6_STATUS_HUMID "湿度ｾﾝｻｽﾃｰﾀｽ
";
CM_ SG_ 995 BIU3E3_2_0_DATA_HUMID_GLA_TMP "湿度(窓ｶﾞﾗｽ温度)ｾﾝｻ
";
CM_ SG_ 995 BIU3E3_1_0_MSG_COUNTER "ﾒｯｾｰｼﾞｶｳﾝﾀ
";
CM_ SG_ 995 BIU3E3_1_4_CSTM_HUMID "湿度ｾﾝｻ有無
";
CM_ SG_ 995 BIU3E3_1_5_COMM_HUMID "湿度ｾﾝｻ通信状態
";
CM_ SG_ 995 BIU3E3_1_7_RX_FAIL_HUMID "LIN通信受信ﾃﾞｰﾀ異常1
";
CM_ SG_ 995 BIU3E3_0_0_CHECK_SUM "ﾁｪｯｸｻﾑ
";
CM_ SG_ 994 BIU3E2_3_0_DATA_SOL_RAD_L "日射ｾﾝｻ左側
";
CM_ SG_ 994 BIU3E2_3_6_FAIL_SOL_RAD_L "日射ｾﾝｻ左側故障
";
CM_ SG_ 994 BIU3E2_3_7_FAIL_SOL_RAD_R "日射ｾﾝｻ右側故障
";
CM_ SG_ 994 BIU3E2_2_0_DATA_SOL_RAD_R "日射ｾﾝｻ右側
";
CM_ SG_ 994 BIU3E2_2_6_STATUS_SOL_RAD "日射(右側/左側)ｾﾝｻｽﾃｰﾀｽ
";
CM_ SG_ 994 BIU3E2_1_0_MSG_COUNTER "ﾒｯｾｰｼﾞｶｳﾝﾀ
";
CM_ SG_ 994 BIU3E2_1_4_CSTM_SOL_RAD "日射ｾﾝｻ有無
";
CM_ SG_ 994 BIU3E2_1_5_COMM_SOL_RAD "日射ｾﾝｻ通信状態
";
CM_ SG_ 994 BIU3E2_1_7_RX_FAIL_SOL_RAD "LIN通信受信ﾃﾞｰﾀ異常1
";
CM_ SG_ 994 BIU3E2_0_0_CHECK_SUM "ﾁｪｯｸｻﾑ
";
CM_ SG_ 942 BIU3AE_5_0_WIPER_FT_VOLUME "ﾄﾞﾗｲﾊﾞAUTO感度設定
";
CM_ SG_ 942 BIU3AE_4_0_DATA_RAINDROP "雨滴情報
";
CM_ SG_ 942 BIU3AE_4_4_FT_WIPER_FAIL "Fﾜｲﾊﾟﾌｪｰﾙ状態
";
CM_ SG_ 942 BIU3AE_4_5_WIPER_FT "FtﾜｲﾊﾟSW状態
";
CM_ SG_ 942 BIU3AE_3_0_WINKER_LEVER_STATUS "ウィンカーレバー状態
";
CM_ SG_ 942 BIU3AE_3_4_WINKER_FACTOR "ｳｨﾝｶｰ出力要因
";
CM_ SG_ 942 BIU3AE_2_0_TURN_LAMP_FAIL_LEFT "メインバルブ異常検知(左)
";
CM_ SG_ 942 BIU3AE_2_1_TURN_LAMP_FAIL_RIGHT "メインバルブ異常検知(右)
";
CM_ SG_ 942 BIU3AE_2_3_HAZARD_SW "ハザードSW状態
";
CM_ SG_ 942 BIU3AE_1_0_MSG_COUNTER "ﾒｯｾｰｼﾞｶｳﾝﾀ
";
CM_ SG_ 942 BIU3AE_0_0_CHECK_SUM "ﾁｪｯｸｻﾑ
";
CM_ SG_ 940 BIU3AC_7_0_HEADLAMP_SMALL "ﾍｯﾄﾞﾗﾝﾌﾟ　ｽﾓｰﾙ
";
CM_ SG_ 940 BIU3AC_7_1_HEADLAMP_LO_REQ "ﾗｲﾃｨﾝｸﾞLo出力要求
";
CM_ SG_ 940 BIU3AC_7_2_HEADLAMP_HI_REQ "ﾗｲﾃｨﾝｸﾞHi出力要求
";
CM_ SG_ 940 BIU3AC_7_3_FT_FOG_RELAY_REQ "Fﾌｫｸﾞﾗﾝﾌﾟﾘﾚｰ出力要求
";
CM_ SG_ 940 BIU3AC_7_4_FOGLAMP_RR "ﾘｱﾌｫｸﾞﾗﾝﾌﾟ
";
CM_ SG_ 940 BIU3AC_7_5_DRL "DRL出力信号
";
CM_ SG_ 940 BIU3AC_7_6_WIPER_FRONT "FTﾜｲﾊﾟ(RTN)
";
CM_ SG_ 940 BIU3AC_7_7_RDEF_RELAY_REQ "ﾘｱﾃﾞﾌｫｯｶﾞ出力要求
";
CM_ SG_ 940 BIU3AC_6_0_RDEFOGSW "ﾘｱﾃﾞﾌｫｯｶﾞSW状態
";
CM_ SG_ 940 BIU3AC_6_1_CSTM_PRG "ﾊﾟﾜｰﾘｱｹﾞｰﾄ有無ﾌﾗｸﾞ
";
CM_ SG_ 940 BIU3AC_6_2_FAIL_SHIFTLOCKSOL "ｼﾌﾄﾛｯｸｿﾚﾉｲﾄﾞ異常
";
CM_ SG_ 940 BIU3AC_6_3_REQ_CANCEL_ISS "ISSｷｬﾝｾﾙ要求
";
CM_ SG_ 940 BIU3AC_6_4_REVERSE_MT "MTﾘﾊﾞｰｽSW
";
CM_ SG_ 940 BIU3AC_6_5_HANDBRAKE "ﾊﾟｰｷﾝｸﾞﾌﾞﾚｰｷSW
";
CM_ SG_ 940 BIU3AC_6_6_BRAKELAMPSW "ﾌﾞﾚｰｷﾗﾝﾌﾟSW
";
CM_ SG_ 940 BIU3AC_6_7_TOWING_SW "ﾄｰｲﾝｸﾞSW
";
CM_ SG_ 940 BIU3AC_5_0_LANE_OFF_SW "LANE OFFｽｲｯﾁ
";
CM_ SG_ 940 BIU3AC_5_2_PCR_OFF_SW "P-CR　OFFｽｲｯﾁ
";
CM_ SG_ 940 BIU3AC_5_4_DIMMER_CANCEL "ﾃﾞｨﾏｰｷｬﾝｾﾙ信号
";
CM_ SG_ 940 BIU3AC_5_5_KEYSW "ｷｰSW
";
CM_ SG_ 940 BIU3AC_5_6_IND_ND_SHIFTLOCK "N-Dｼﾌﾄﾛｯｸ用ﾌﾞﾚｰｷ押下表示有無
";
CM_ SG_ 940 BIU3AC_4_0_DOOR_DRVR "ﾄﾞｱSW　D席
";
CM_ SG_ 940 BIU3AC_4_1_DOOR_PASS "ﾄﾞｱSW　P席
";
CM_ SG_ 940 BIU3AC_4_2_DOOR_RRRH "ﾄﾞｱSW　後席右
";
CM_ SG_ 940 BIU3AC_4_3_DOOR_RRLH "ﾄﾞｱSW　後席左
";
CM_ SG_ 940 BIU3AC_4_4_DOOR_RG "ﾄﾞｱSW　Rｹﾞｰﾄ
";
CM_ SG_ 940 BIU3AC_4_5_DOOR_TR "ﾄﾞｱSW　ﾄﾗﾝｸ
";
CM_ SG_ 940 BIU3AC_4_6_HOOD_CLOSE "ﾌｰﾄﾞSW　閉側
";
CM_ SG_ 940 BIU3AC_4_7_HOOD_OPEN "ﾌｰﾄﾞＳＷ　開側
";
CM_ SG_ 940 BIU3AC_3_0_GW_STSW_RES "RESからのSTSWﾃﾞｰﾀ
";
CM_ SG_ 940 BIU3AC_3_1_GW_POWER_RES "SMTからのﾘﾓｽﾀ電源ONﾃﾞｰﾀ
";
CM_ SG_ 940 BIU3AC_3_3_ST1 "STﾌﾗｸﾞ1
";
CM_ SG_ 940 BIU3AC_3_4_ST2 "STﾌﾗｸﾞ2
";
CM_ SG_ 940 BIU3AC_3_5_ACC "ACC
";
CM_ SG_ 940 BIU3AC_3_6_IGA "IG-a
";
CM_ SG_ 940 BIU3AC_3_7_BAT_BACKUP "B/up
";
CM_ SG_ 940 BIU3AC_2_0_CSTM_AC "A/C　ＣＡＮ接続有無ﾌﾗｸﾞ
";
CM_ SG_ 940 BIU3AC_2_1_IMB_SMT "IM/SMT判別情報
";
CM_ SG_ 940 BIU3AC_2_3_CSTM_WGN_SDN "WGN/SDN判別ﾌﾗｸﾞ
";
CM_ SG_ 940 BIU3AC_2_4_VAL_SEAT_BACK_CTSM "ｼｰﾄ現在設定値
";
CM_ SG_ 940 BIU3AC_2_5_VAL_MIR_AFOLD_CTSM "ﾐﾗｰ電格設定値
";
CM_ SG_ 940 BIU3AC_2_6_VAL_MIR_RTILT_CTSM "R連動ﾐﾗｰ設定値
";
CM_ SG_ 940 BIU3AC_2_7_WIPER_REAR "RRﾜｲﾊﾟ(RTN)
";
CM_ SG_ 940 BIU3AC_1_0_MSG_COUNTER "ﾒｯｾｰｼﾞｶｳﾝﾀ
";
CM_ SG_ 940 BIU3AC_1_4_PADDLESHIFT_DOWN_SW "ﾊﾟﾄﾞﾙｼﾌﾄﾀﾞｳﾝSW
";
CM_ SG_ 940 BIU3AC_1_5_PADDLESHIFT_UP_SW "ﾊﾟﾄﾞﾙｼﾌﾄｱｯﾌﾟSW
";
CM_ SG_ 940 BIU3AC_1_6_MANUALMODE_SW "ﾏﾆｭｱﾙﾓｰﾄﾞSW
";
CM_ SG_ 940 BIU3AC_0_0_CHECK_SUM "ﾁｪｯｸｻﾑ
";
CM_ SG_ 1286 BIU506_1_4_ActiveWakeUpBit "Active Wakeup ﾌﾗｸﾞ
";
CM_ SG_ 1286 BIU506_0_0_SourceNodeID "送信元ID
";
CM_ SG_ 1616 BIU650_7_0_Reserved "ワイパーサービスモードSW操作禁止フラグ
";
CM_ SG_ 1616 BIU650_7_1_Reserved "ワイパーサービスモード有無フラグ
";
CM_ SG_ 1616 BIU650_7_2_Reserved "ワイパーサービスモード状態
";
CM_ SG_ 1616 BIU650_7_3_DOOR_LINK_SW_STS "室内灯DOOR連動SW状態
";
CM_ SG_ 1616 BIU650_7_4_Reserved "ウィンドウロックSW信号
";
CM_ SG_ 1616 BIU650_6_0_Reserved "オートライト感度調整設定値
";
CM_ SG_ 1616 BIU650_6_3_RR_WIPER_STATUS "Ｒワイパ駆動状態
";
CM_ SG_ 1616 BIU650_6_5_WIPER_SENSITIVITY_CTM "ワイパ感度設定
";
CM_ SG_ 1616 BIU650_5_0_Reserved "ﾄﾞｱSW運転席信号
";
CM_ SG_ 1616 BIU650_5_1_Reserved "全ﾄﾞｱ開閉変化ｲﾍﾞﾝﾄ判定
";
CM_ SG_ 1616 BIU650_5_2_FMH_DOOR_LOCK "フォローミーホームドアロック判定
";
CM_ SG_ 1616 BIU650_5_4_LMH_DOOR_LOCK "リードミーホームドアロック判定
";
CM_ SG_ 1616 BIU650_4_0_REQ_OPE_AUTOLIGHT "オートライト点灯/消灯要求
";
CM_ SG_ 1616 BIU650_4_2_STATE_SHINSSR "ライトセンサステータス
";
CM_ SG_ 1616 BIU650_4_4_STATE_RLS_FAIL "RLS異常状態
";
CM_ SG_ 1616 BIU650_3_0_REQ_FWASHER_ITLOCK "F ウォッシャ連動要求
";
CM_ SG_ 1616 BIU650_3_1_FWIPER_RTN "F ワイパ（RTN)補正
";
CM_ SG_ 1616 BIU650_3_2_TURN_LAMP_STATE_LEFT "左ターンランプ状態
";
CM_ SG_ 1616 BIU650_3_3_TURN_LAMP_STATE_RIGHT "右ターンランプ状態
";
CM_ SG_ 1616 BIU650_3_4_Reserved "RES操作ﾗｲﾃｨﾝｸﾞ1出力要求
";
CM_ SG_ 1616 BIU650_2_0_HEADLAMP_SMALL_SW "ライティング1SW信号
";
CM_ SG_ 1616 BIU650_2_1_HEADLAMP_LO_SW "ライティング2SW信号
";
CM_ SG_ 1616 BIU650_2_2_HEADLAMP_OFF_SW "ライティングOFF SW信号
";
CM_ SG_ 1616 BIU650_2_3_HEADLAMP_Hi_SW "ディマーHi SW 信号
";
CM_ SG_ 1616 BIU650_2_4_HEAD_LAMP_PASS_SW "ディマーPass SW 信号
";
CM_ SG_ 1616 BIU650_2_5_FFOG_SW "FフォグランプSW信号
";
CM_ SG_ 1616 BIU650_2_6_RFOG_SW "RフォグランプSW信号
";
CM_ SG_ 1616 BIU650_1_0_MSG_COUNTER "メッセージカウンタ
";
CM_ SG_ 1616 BIU650_0_0_CHECK_SUM "チェックサム
";
CM_ SG_ 1615 BIU64F_4_0 "吹鳴回数
";
CM_ SG_ 1615 BIU64F_3_0 "音量
";
CM_ SG_ 1615 BIU64F_2_0 "吹鳴要求パターン
";
CM_ SG_ 1615 BIU64F_1_0_MSG_COUNTER "ﾒｯｾｰｼﾞｶｳﾝﾀ
";
CM_ SG_ 1615 BIU64F_0_0_CHECK_SUM "ﾁｪｯｸｻﾑ
";
CM_ SG_ 859 DAM35B_7_0_VERTICAL_ACCELERATION "上下加速度
";
CM_ SG_ 859 DAM35B_6_0_ROLL_SPEED "ロール
";
CM_ SG_ 859 DAM35B_5_0_PITCH_SPEED "ピッチ
";
CM_ SG_ 859 DAM35B_4_0_EYE_CONTROL_FLAG "EYEコントロールフラグ
";
CM_ SG_ 859 DAM35B_3_0_WARNING_LAMP "警告灯
";
CM_ SG_ 859 DAM35B_3_2_DAMPER_MODE "ダンパーモード
";
CM_ SG_ 859 DAM35B_3_5_FAIL_FLAG_FOR_CCU "CCU向けフェールフラグ
";
CM_ SG_ 859 DAM35B_3_6_FAIL_FLAG_DAMPER "ダンパーフェールフラグ
";
CM_ SG_ 859 DAM35B_1_0_MSG_COUNTER "メッセージカウンタ
";
CM_ SG_ 859 DAM35B_0_0_CHECK_SUM "チェックサム
";
CM_ SG_ 1368 DAM558_0_0_NETWORK_STATUS "ﾈｯﾄﾜｰｸｽﾃｰﾀｽ
";
CM_ SG_ 811 EPB32B_7_0_AVH_TARGET_PRESS "AVH目標保持圧
";
CM_ SG_ 811 EPB32B_6_0_VEHICLE_RUN_STOP_FLG "車両走行停止判定ﾌﾗｸﾞ
";
CM_ SG_ 811 EPB32B_6_2_REQ_HILL_P_CAUTION "坂道駐車警告表示要求
";
CM_ SG_ 811 EPB32B_5_0_FLG_AVH_OILPRES_EPB "AVH制御ﾌﾗｸﾞ(液圧/EPB)
";
CM_ SG_ 811 EPB32B_5_1_FLG_AVH "AVH作動ﾌﾗｸﾞ
";
CM_ SG_ 811 EPB32B_5_2_AVH_INTENSIFY_PRES "ISS中AVH中増圧ﾌﾗｸﾞ
";
CM_ SG_ 811 EPB32B_5_3_BREAK_IND "ﾌﾞﾚｰｷ踏み指示
";
CM_ SG_ 811 EPB32B_5_5_AVH_ON_LAMP "AVH_ON灯
";
CM_ SG_ 811 EPB32B_5_6_AVH_FUNC_ON_LUMP "AVH 作動灯
";
CM_ SG_ 811 EPB32B_5_7_AVH_ACTIVE "AVH有無ﾌﾗｸﾞ
";
CM_ SG_ 811 EPB32B_4_0_BUZZER "ﾌﾞｻﾞｰ
";
CM_ SG_ 811 EPB32B_4_2_HILL_HOLD_ON_LAMP "ﾋﾙﾎｰﾙﾄﾞ機能ONﾗﾝﾌﾟ
";
CM_ SG_ 811 EPB32B_4_3_CLAMP_LAMP "EPB作動灯
";
CM_ SG_ 811 EPB32B_4_5_WARN_LAMP "EPB警告灯
";
CM_ SG_ 811 EPB32B_4_7_WARN_EPB_MET_LCD "ﾒｰﾀ内液晶用EPB警告灯
";
CM_ SG_ 811 EPB32B_3_0_STATUS_EPB "EPB作動状態
";
CM_ SG_ 811 EPB32B_3_3_DYNAMIC_PARKING "動的ﾊﾟｰｷﾝｸﾞﾌﾗｸﾞ
";
CM_ SG_ 811 EPB32B_3_4_HILL_HOLD_RUN_FLG "ﾋﾙﾎｰﾙﾄﾞ作動ﾌﾗｸﾞ
";
CM_ SG_ 811 EPB32B_3_5_INHIBIT_ISS_DELAY "ISS作動禁止要求ﾌﾗｸﾞ(判定ﾃﾞｨﾚｲ有り)
";
CM_ SG_ 811 EPB32B_3_6_INHIBIT_ISS "ISS作動禁止要求ﾌﾗｸﾞ(判定ﾃﾞｨﾚｲ無し)
";
CM_ SG_ 811 EPB32B_3_7_AVH_PERMIT_CONT_ACC "AVH-ACC協調許可フラグ
";
CM_ SG_ 811 EPB32B_2_0_ERR_INFO "EPBｴﾗｰ情報
";
CM_ SG_ 811 EPB32B_2_2_EPB_FAIL_FLG1 "EPBﾌｪｰﾙﾌﾗｸﾞ1
";
CM_ SG_ 811 EPB32B_2_3_EPB_FAIL_FLG2 "EPBﾌｪｰﾙﾌﾗｸﾞ2
";
CM_ SG_ 811 EPB32B_2_4_EPB_FAIL_FLG3 "EPBﾌｪｰﾙﾌﾗｸﾞ3
";
CM_ SG_ 811 EPB32B_1_0_MSG_COUNTER "ﾒｯｾｰｼﾞｶｳﾝﾀ
";
CM_ SG_ 811 EPB32B_1_4_WAKE_UP_FRAME "ｳｪｲｸｱｯﾌﾟﾌﾚｰﾑ識別ﾌﾗｸﾞ
";
CM_ SG_ 811 EPB32B_1_5_REQ_COMM_CONT "通信継続要求ﾌﾗｸﾞ
";
CM_ SG_ 811 EPB32B_1_6 "予約:通信継続要求ﾌﾗｸﾞ(拡張)
";
CM_ SG_ 811 EPB32B_0_0_CHECK_SUM "ﾁｪｯｸｻﾑ
";
CM_ SG_ 323 VDC143_3_0_VEHICLE_SPEED "車両速度
";
CM_ SG_ 323 VDC143_2_0_P_EXT_MAX "4輪の車輪液圧推定値の最大値
";
CM_ SG_ 323 VDC143_1_0_MSG_COUNTER "メッセージカウンタ
";
CM_ SG_ 323 VDC143_1_4_IG_ON "VDCイグニッションON/OFF情報
";
CM_ SG_ 323 VDC143_1_5_VEHICLE_SPEED_Q "車両速度ステータス信号
";
CM_ SG_ 323 VDC143_1_7_DIAG_STATUS "VDC DIAG状態フラグ
";
CM_ SG_ 323 VDC143_0_0_CHECK_SUM "チェックサム
";
CM_ SG_ 362 VDC16A_6_0_ACCELERATE_F_R_R160 "前後Gｾﾝｻ値(UN-R160-01用)
";
CM_ SG_ 362 VDC16A_4_0_YAW_RATE_HI_RES "ヨーレート(高分解能)
";
CM_ SG_ 362 VDC16A_3_7_JUDGE_EXTRUSION "押し出し判定ﾌﾗｸﾞ
";
CM_ SG_ 362 VDC16A_2_0_ACCELERATE_L_R_HI_RES "横加速度(高分解能)
";
CM_ SG_ 362 VDC16A_1_0_MSG_COUNTER "メッセージカウンタ
";
CM_ SG_ 362 VDC16A_0_0_CHECK_SUM "チェックサム
";
CM_ SG_ 316 VDC13C_7_0_RCV_FAIL_ADA "ADA FAIL　受信
";
CM_ SG_ 316 VDC13C_7_1_FAIL_PCU "PCU通信異常
";
CM_ SG_ 316 VDC13C_7_2_CONT_STATE_ES_BRAKE "ACCブレーキ制御状態
";
CM_ SG_ 316 VDC13C_7_3_ASST_PRECRUSH_ACC "ACCﾌﾟﾘｸﾗﾌﾞﾚｰｷｱｼｽﾄ作動ﾌﾗｸﾞ
";
CM_ SG_ 316 VDC13C_7_4_CONT_STATE_PRECRUSH "プリクラ制御状態
";
CM_ SG_ 316 VDC13C_7_5_PERMIT_BRAKE_ACC "ACCﾌﾞﾚｰｷ制御許可ﾌﾗｸﾞ
";
CM_ SG_ 316 VDC13C_7_6_DETECT_BRAKING "ﾄﾞﾗｲﾊﾞﾌﾞﾚｰｷ検出ﾌﾗｸﾞ
";
CM_ SG_ 316 VDC13C_7_7_EMERGENCY_BRAKE "緊急ﾌﾞﾚｰｷｼｸﾞﾅﾙ
";
CM_ SG_ 316 VDC13C_6_0_SPD_PULSE_INTEGRAL "車速ﾊﾟﾙｽ信号積算値（SP1P）
";
CM_ SG_ 316 VDC13C_6_6_VDC_OFF "VDC OFFﾌﾗｸﾞ
";
CM_ SG_ 316 VDC13C_6_7_STBY_PREVIEW_VDC "ﾌﾟﾚﾋﾞｭｰVDCｽﾀﾝﾊﾞｲﾌﾗｸﾞ
";
CM_ SG_ 316 VDC13C_5_0_SPD_PULSE_RRRH "右後輪車輪速ﾊﾟﾙｽ信号(生ﾊﾟﾙｽ値)
";
CM_ SG_ 316 VDC13C_5_7_ACTIVATE_TSM "TSM作動ﾌﾗｸﾞ
";
CM_ SG_ 316 VDC13C_4_0_SPD_PULSE_RRLH "左後輪車輪速ﾊﾟﾙｽ信号(生ﾊﾟﾙｽ値)
";
CM_ SG_ 316 VDC13C_4_7_ACTIVATE_RMI "RMI作動ﾌﾗｸﾞ
";
CM_ SG_ 316 VDC13C_3_0_SPD_PULSE_FTRH "右前輪車輪速ﾊﾟﾙｽ信号(生ﾊﾟﾙｽ値)
";
CM_ SG_ 316 VDC13C_3_7_ACTIVATE_VECTARING "ﾌﾞﾚｰｷﾍﾞｸﾀﾘﾝｸﾞ制御作動ﾌﾗｸﾞ
";
CM_ SG_ 316 VDC13C_2_0_SPD_PULSE_FTLH "左前輪車輪速ﾊﾟﾙｽ信号(生ﾊﾟﾙｽ値)
";
CM_ SG_ 316 VDC13C_2_7_STATE_ACTIVATE_HSA "HSA作動状態信号
";
CM_ SG_ 316 VDC13C_1_0_MSG_COUNTER "ﾒｯｾｰｼﾞｶｳﾝﾀ
";
CM_ SG_ 316 VDC13C_1_4_ACTIVE_BRAKEHOLD "ﾌﾞﾚｰｷﾎｰﾙﾄﾞ作動ﾌﾗｸﾞ
";
CM_ SG_ 316 VDC13C_1_5_PROHIBIT_BRAKEHOLD "ﾌﾞﾚｰｷﾎｰﾙﾄﾞ禁止ﾌﾗｸﾞ
";
CM_ SG_ 316 VDC13C_1_6_BRAKELAMP_RELAY "ﾌﾞﾚｰｷﾗﾝﾌﾟﾘﾚｰ駆動信号
";
CM_ SG_ 316 VDC13C_1_7_STATUS_BRAKELAMP "ﾌﾞﾚｰｷﾗﾝﾌﾟ状態ﾌﾗｸﾞ
";
CM_ SG_ 316 VDC13C_0_0_CHECK_SUM "ﾁｪｯｸｻﾑ
";
CM_ SG_ 315 VDC13B_7_0_ACCELERATE_F_R "前後Gｾﾝｻ値
";
CM_ SG_ 315 VDC13B_6_0_ACCELERATE_L_R "横加速度
";
CM_ SG_ 315 VDC13B_4_0_ENG_TRQ_DOWN "ｴﾝｼﾞﾝﾄﾙｸ減少要求値
";
CM_ SG_ 315 VDC13B_2_0_ENG_TRQ_UP "ｴﾝｼﾞﾝﾄﾙｸｱｯﾌﾟ要求値
";
CM_ SG_ 315 VDC13B_1_0_MSG_COUNTER "ﾒｯｾｰｼﾞｶｳﾝﾀ
";
CM_ SG_ 315 VDC13B_1_4_BRAKE_TYPE "ﾌﾞﾚｰｷｼｽﾃﾑﾌﾗｸﾞ
";
CM_ SG_ 315 VDC13B_1_5_REQ_ENG_TRQ_DOWN "ｴﾝｼﾞﾝﾄﾙｸ減少要求ﾌﾗｸﾞ
";
CM_ SG_ 315 VDC13B_1_6_REQ_ENG_TRQ_UP "ｴﾝｼﾞﾝﾄﾙｸｱｯﾌﾟ要求ﾌﾗｸﾞ
";
CM_ SG_ 315 VDC13B_1_7_PROHIBIT_FUEL_CUT "ﾌｭｰｴﾙｶｯﾄ禁止ﾌﾗｸﾞ
";
CM_ SG_ 315 VDC13B_0_0_CHECK_SUM "ﾁｪｯｸｻﾑ
";
CM_ SG_ 313 VDC139_7_4_FAIL_PRESSURE_SSR "圧力ｾﾝｻ故障ﾌﾗｸﾞ
";
CM_ SG_ 313 VDC139_7_5_STATUS_EPB "EPB作動状態
";
CM_ SG_ 313 VDC139_6_0_SSR_N_PRESS "負圧ｾﾝｻ値
";
CM_ SG_ 313 VDC139_5_0_PRESSURE_BRAKE "ﾌﾞﾚｰｷ圧力
";
CM_ SG_ 313 VDC139_4_0_HDC_STATUS "HDC状態信号
";
CM_ SG_ 313 VDC139_4_2_BRAKELAMPSW "BLS信号
";
CM_ SG_ 313 VDC139_4_3_FAIL_BRAKELAMPSW "BLS故障信号
";
CM_ SG_ 313 VDC139_4_4_ACTIVATE_ABS "ABS作動ﾌﾗｸﾞ
";
CM_ SG_ 313 VDC139_4_5_ACTIVATE_TCS "TCS作動ﾌﾗｸﾞ
";
CM_ SG_ 313 VDC139_4_6_CONT_OVER_STR "VDCｵｰﾊﾞｰ制御ﾌﾗｸﾞ
";
CM_ SG_ 313 VDC139_4_7_CONT_UNDER_STR "VDCｱﾝﾀﾞｰ制御ﾌﾗｸﾞ
";
CM_ SG_ 313 VDC139_3_5_FAIL_VDC_SSR "VDCｾﾝｻﾌｪｰﾙﾌﾗｸﾞ
";
CM_ SG_ 313 VDC139_3_6_FAIL_SPD_SSR_FHI "ｽﾋﾟｰﾄﾞｾﾝｻﾌｪｰﾙﾌﾗｸﾞ（FHI）
";
CM_ SG_ 313 VDC139_3_7_FAIL_ABS_SYS "ABSｼｽﾃﾑﾌｪｰﾙﾌﾗｸﾞ
";
CM_ SG_ 313 VDC139_2_0_SPD_WHEEL_AVE "駆動輪軸平均車輪速（VSO）
";
CM_ SG_ 313 VDC139_1_0_MSG_COUNTER "ﾒｯｾｰｼﾞｶｳﾝﾀ
";
CM_ SG_ 313 VDC139_1_4_FAIL_HDC_SYS "HDCｼｽﾃﾑﾌｪｰﾙﾌﾗｸﾞ
";
CM_ SG_ 313 VDC139_1_5_VEHICLE_HIGHT "車高情報
";
CM_ SG_ 313 VDC139_1_7_REPROGRAMING "CAN診断・送信停止
";
CM_ SG_ 313 VDC139_0_0_CHECK_SUM "ﾁｪｯｸｻﾑ
";
CM_ SG_ 312 VDC138_7_0_PRESSURE_WC_FTLH "FL W/C実液圧
";
CM_ SG_ 312 VDC138_6_0_PRESSURE_WC_FTRH "FR W/C実液圧
";
CM_ SG_ 312 VDC138_4_0_YAW_RATE "ﾖｰﾚｰﾄ
";
CM_ SG_ 312 VDC138_2_0_STEER_ANGLE "舵角ｾﾝｻ
";
CM_ SG_ 312 VDC138_1_0_MSG_COUNTER "ﾒｯｾｰｼﾞｶｳﾝﾀ
";
CM_ SG_ 312 VDC138_1_4_ACTIVE_LDP "LDP作動ﾌﾗｸﾞ
";
CM_ SG_ 312 VDC138_1_5_PROHIBIT_LDP "LDP禁止ﾌﾗｸﾞ
";
CM_ SG_ 312 VDC138_1_6_VDC_SMALL_MARGIN "VDC介入余裕小ﾌﾗｸﾞ
";
CM_ SG_ 312 VDC138_1_7_DETECT_REAR_SLIP "ﾘｱｽﾘｯﾌﾟ検出ﾌﾗｸﾞ
";
CM_ SG_ 312 VDC138_0_0_CHECK_SUM "ﾁｪｯｸｻﾑ
";
CM_ SG_ 946 IPMS3B2_5_0_STATUS_IMPAIR_DRV "ドライバー異常状態判定機能ON/OFF状態
";
CM_ SG_ 946 IPMS3B2_5_1_VALID_IMPAIR_DRV "ドライバー異常状態判定参照可否
";
CM_ SG_ 946 IPMS3B2_5_2_JUDGE_IMPAIR_DRV "ドライバー異常状態判定
";
CM_ SG_ 946 IPMS3B2_2_0_STATUS_DIST_FAT_WARN "脇見・居眠り警報機能ON/OFF状態
";
CM_ SG_ 946 IPMS3B2_1_0_MSG_COUNTER "メッセージカウンタ
";
CM_ SG_ 946 IPMS3B2_1_4_FAIL_IPMS "IPMS故障通知
";
CM_ SG_ 946 IPMS3B2_0_0_CHECK_SUM "チェックサム
";
CM_ SG_ 952 CCU3B8_6_0_ACPANEL_STEER_H_LINK "ステアリングヒータAUTO連動カスタマイズ
";
CM_ SG_ 952 CCU3B8_5_6_ACPANEL_SEAT_H_LINK_P "P席 シートヒータ空調AUTO連動カスタマイズ
";
CM_ SG_ 952 CCU3B8_5_4_ACPANEL_SEAT_H_LINK_D "D席 シートヒータ空調AUTO連動カスタマイズ
";
CM_ SG_ 952 CCU3B8_4_3_ACPANEL_SEAT_V_TEMP_P "P席シートベンチレーション温度カスタマイズ
";
CM_ SG_ 952 CCU3B8_4_0_ACPANEL_SEAT_V_TEMP_D "D席シートベンチレーション温度カスタマイズ
";
CM_ SG_ 952 CCU3B8_3_7_ACN_CSTM_REQ "ACNカスタマイズ変更要求
";
CM_ SG_ 952 CCU3B8_3_3_ACPANEL_SEAT_H_TEMP_P "P席シートヒータ温度カスタマイズ
";
CM_ SG_ 952 CCU3B8_3_0_ACPANEL_SEAT_H_TEMP_D "D席シートヒータ温度カスタマイズ
";
CM_ SG_ 952 CCU3B8_2_0_ACPANEL_FAN_ONLY_SW "エアコンパネル 送風モードSW情報
";
CM_ SG_ 952 CCU3B8_2_1_ACPANEL_INNER_AIR "ｴｱｺﾝﾊﾟﾈﾙ 内外気
";
CM_ SG_ 952 CCU3B8_1_6_ACPANEL_AUTO_ECO_SW "エアコンパネル Auto 3 SW情報
";
CM_ SG_ 952 CCU3B8_1_4_STEER_HEAT_SW "ステアリングヒータSW情報
";
CM_ SG_ 952 CCU3B8_1_0_MSG_COUNTER "ﾒｯｾｰｼﾞｶｳﾝﾀ
";
CM_ SG_ 952 CCU3B8_0_0_CHECK_SUM "チェックサム
";
CM_ SG_ 1710 CCU6AE_2_4_DEST_PRD_NUM "CCU仕向地品番
";
CM_ SG_ 1710 CCU6AE_2_2_VDC_SW_INFO "VDC SW情報
";
CM_ SG_ 1710 CCU6AE_2_0_ISS_SW_INFO "ISS SW情報
";
CM_ SG_ 1710 CCU6AE_1_0_MSG_COUNTER "メッセージカウンタ
";
CM_ SG_ 1710 CCU6AE_0_0_CHECK_SUM "チェックサム
";
CM_ SG_ 1707 CCU6AB_7_3_REQ_RESET_CSTM_TPM "カスタマイズリセット要求(TPM)
";
CM_ SG_ 1707 CCU6AB_7_2_TPM_CSTM_CHG_REQ "TPMカスタマイズ要求変更
";
CM_ SG_ 1707 CCU6AB_7_0_CSTM_TIRE_UNIT "タイヤ空気圧表示単位設定
";
CM_ SG_ 1707 CCU6AB_6_3_REQ_RESET_CSTM_AHL "カスタマイズリセット要求(AHL)
";
CM_ SG_ 1707 CCU6AB_6_2_SRH_CSTM_CHG_REQ "SHRカスタマイズ要求変更
";
CM_ SG_ 1707 CCU6AB_6_0_SRH_CSTM_CHG_SET "SRHカスタマイズ変更設定
";
CM_ SG_ 1707 CCU6AB_5_0_SEATAWAY_DST_CSTM "シート後退量変更要求
";
CM_ SG_ 1707 CCU6AB_5_2_DRIVER_POSI_REQ "ドラポジ操作要求
";
CM_ SG_ 1707 CCU6AB_5_6_OCCUPANT_DETECT_REQ "乗員検知設定切替要求
";
CM_ SG_ 1707 CCU6AB_4_6_AFOLD_SW_MIR_SW "ミラコンSW：電格SW変更要求
";
CM_ SG_ 1707 CCU6AB_4_2_MIR_DIRECTION_MIR_SW "ミラコンSW：鏡面SW上下左右変更要求
";
CM_ SG_ 1707 CCU6AB_4_0_MIR_SELECT_LR_MIR_SW "ミラコンSW：鏡面SW左右選択変更要求
";
CM_ SG_ 1707 CCU6AB_3_0_PRG_OPENER_SW "PRG 運転席オープナSW 信号
";
CM_ SG_ 1707 CCU6AB_3_1_PRG_MEM_CHG_REQ "PRGメモリON/OFF設定変更要求
";
CM_ SG_ 1707 CCU6AB_3_2_PRG_HF_CHG_REQ "PRGハンズフリーON/OFF設定変更要求
";
CM_ SG_ 1707 CCU6AB_3_6_MIR_RTILT_R_CSTM "リバース連動機能ドアミラー右　設定変更要求
";
CM_ SG_ 1707 CCU6AB_3_7_MIR_RTILT_L_CSTM "リバース連動機能ドアミラー左　設定変更要求
";
CM_ SG_ 1707 CCU6AB_2_6_WASH_CAR_MODE_REQ "洗車モード切替要求
";
CM_ SG_ 1707 CCU6AB_2_4_SHUT_DOWN_MODE_REQ "シャットダウンモード切替要求
";
CM_ SG_ 1707 CCU6AB_2_2_PET_MODE_SWITCH_REQ "ペットモード切替要求
";
CM_ SG_ 1707 CCU6AB_2_0_POW_ON_FIX_MODE_REQ "電源ON固定モード切替要求
";
CM_ SG_ 1707 CCU6AB_1_7_CECU_CSTM_RESET_REQ "C-ECUカスタマイズリセット要求
";
CM_ SG_ 1707 CCU6AB_1_0_MSG_COUNTER "メッセージカウンタ
";
CM_ SG_ 1707 CCU6AB_0_0_CHECK_SUM "チェックサム
";
CM_ SG_ 1706 CCU6AA_5_0_WINDOW_LOCK_SET_REQ "ウィンドウロック変更要求
";
CM_ SG_ 1706 CCU6AA_5_2_DOOR_LINK_SET_REQ "室内灯ドア連動変更要求
";
CM_ SG_ 1706 CCU6AA_5_4_BULK_TURN_ON_REQ "室内灯一括点灯変更要求
";
CM_ SG_ 1706 CCU6AA_5_6_WIPER_SERV_MODE_REQ "ワイパーサービスモード変更要求
";
CM_ SG_ 1706 CCU6AA_4_0_ITMITT_SENSITIVE_REQ "ワイパー感度変更要求
";
CM_ SG_ 1706 CCU6AA_4_4_REAR_WIPER_SET_REQ "リアワイパー変更要求
";
CM_ SG_ 1706 CCU6AA_4_7_SMT_CSTM_RESET_REQ "SMTカスタマイズリセット要求
";
CM_ SG_ 1706 CCU6AA_3_0_WELCOME_RIDEON_REQ "ウェルカムランプ乗車時作動時間変更要求
";
CM_ SG_ 1706 CCU6AA_3_3_WELCOME_GETOFF_REQ "ウェルカムランプ降車時作動時間変更要求
";
CM_ SG_ 1706 CCU6AA_2_0_WIPER_HEADLAMP_REQ "ワイパー連動ヘッドランプ変更要求
";
CM_ SG_ 1706 CCU6AA_1_0_MSG_COUNTER "メッセージカウンタ
";
CM_ SG_ 1706 CCU6AA_1_4_WIUL_CUSTOM_REQ "WIUL変更要求
";
CM_ SG_ 1706 CCU6AA_1_6_WAL_CUSTOM_REQ "WAL変更要求
";
CM_ SG_ 1706 CCU6AA_0_0_CHECK_SUM "チェックサム
";
CM_ SG_ 1704 CCU6A8_7_5_TRQ_CHG_MODE_SET "トルク変動モード変更要求
";
CM_ SG_ 1704 CCU6A8_7_3_ADAPT_DEC_CHG_REQ "Adaptive変更要求
";
CM_ SG_ 1704 CCU6A8_7_0_DEC_SELECT_REQ_B "減速度セレクト変更要求_B
";
CM_ SG_ 1704 CCU6A8_6_5_DEC_SELECT_REQ_D "減速度セレクト変更要求_D
";
CM_ SG_ 1704 CCU6A8_6_2_DEC_SELECT_REQ_ALL "減速度セレクト変更要求_ALL
";
CM_ SG_ 1704 CCU6A8_6_0_DEC_SELECT_REQ_IND "減速度セレクト変更要求_Individual
";
CM_ SG_ 1704 CCU6A8_5_2_TOWING_MODE_REQ "トーイングモード変更要求
";
CM_ SG_ 1704 CCU6A8_5_0_FACTORY_MODE_STATE "工場状態モード
";
CM_ SG_ 1704 CCU6A8_4_2_TRIP_RESET_REQ "トリップリセット要求
";
CM_ SG_ 1704 CCU6A8_4_0_TRIP_SWITCH_REQ "トリップ切替要求
";
CM_ SG_ 1704 CCU6A8_3_0_DOW_SFT_POS_SET "DOW有効シフトポジション設定値
";
CM_ SG_ 1704 CCU6A8_2_6_DOW_SET "DOW設定値
";
CM_ SG_ 1704 CCU6A8_2_4_RCTA_SET "RCTA設定値
";
CM_ SG_ 1704 CCU6A8_2_2_BSD_LCA_2ND_SET "BSD/LCA2次警報音カスタマイズ設定値
";
CM_ SG_ 1704 CCU6A8_2_0_SRVD_SET "SRVD設定値
";
CM_ SG_ 1704 CCU6A8_1_6_RCR_CSTM_RESET_REQ "RCRカスタマイズリセット要求
";
CM_ SG_ 1704 CCU6A8_1_4_BEV_CSTM_RESET_REQ "BEVカスタマイズリセット要求
";
CM_ SG_ 1704 CCU6A8_1_0_MSG_COUNTER "メッセージカウンタ
";
CM_ SG_ 1704 CCU6A8_0_0_CHECK_SUM "チェックサム
";
CM_ SG_ 1649 MCL671_3_4_MIR_SEN_H_ANOMALOUS "鏡面センサ異常(左右)
";
CM_ SG_ 1649 MCL671_3_5_MIR_SEN_V_ANOMALOUS "鏡面センサ異常(上下)
";
CM_ SG_ 1649 MCL671_2_0_NVM_ANOMALOUS "不揮発性メモリ異常
";
CM_ SG_ 1649 MCL671_2_1_POWER_ANOMALOUS "電源電圧異常
";
CM_ SG_ 1649 MCL671_1_0_MSG_COUNTER "メッセージカウンタ
";
CM_ SG_ 1649 MCL671_0_0_CHECK_SUM "チェックサム
";
CM_ SG_ 1648 MCL670_4_0_STATE_ACT_HTR_LMR "Lミラーヒータ：　作動状態
";
CM_ SG_ 1648 MCL670_3_0_STATE_ACT_CTL_L "Lカーテシランプ：　作動状態
";
CM_ SG_ 1648 MCL670_2_0_MCL_APPLY_CONST "MCL：適用定数
";
CM_ SG_ 1648 MCL670_1_0_MSG_COUNTER "メッセージカウンタ
";
CM_ SG_ 1648 MCL670_0_0_CHECK_SUM "チェックサム
";
CM_ SG_ 1647 MCL66F_7_0_CUR_POS_H_MIR_LMR "L鏡面：　現在位置H
";
CM_ SG_ 1647 MCL66F_5_0_CUR_POS_V_MIR_LMR "L鏡面：　現在位置V
";
CM_ SG_ 1647 MCL66F_3_0_STATE_ACT_MIR_LMR "L鏡面：　作動状態
";
CM_ SG_ 1647 MCL66F_2_0_CUR_POS_AFOLD_LMR "L電格：　現在位置
";
CM_ SG_ 1647 MCL66F_2_2_STATE_ACT_AFOLD_LMR "L電格：　作動状態
";
CM_ SG_ 1647 MCL66F_1_0_MSG_COUNTER "メッセージカウンタ
";
CM_ SG_ 1647 MCL66F_0_0_CHECK_SUM "チェックサム
";
CM_ SG_ 1644 MCR66C_3_4_MIR_SEN_H_ANOMALOUS "鏡面センサ異常(左右)
";
CM_ SG_ 1644 MCR66C_3_5_MIR_SEN_V_ANOMALOUS "鏡面センサ異常(上下)
";
CM_ SG_ 1644 MCR66C_2_0_NVM_ANOMALOUS "不揮発性メモリ異常
";
CM_ SG_ 1644 MCR66C_2_1_POWER_ANOMALOUS "電源電圧異常
";
CM_ SG_ 1644 MCR66C_1_0_MSG_COUNTER "メッセージカウンタ
";
CM_ SG_ 1644 MCR66C_0_0_CHECK_SUM "チェックサム
";
CM_ SG_ 1643 MCR66B_4_0_STATE_ACT_HTR_RMR "Rミラーヒータ：　作動状態
";
CM_ SG_ 1643 MCR66B_3_0_STATE_ACT_CTL_R "Rカーテシランプ：　作動状態
";
CM_ SG_ 1643 MCR66B_2_0_MCR_APPLY_CONST "MCR：適用定数
";
CM_ SG_ 1643 MCR66B_1_0_MSG_COUNTER "メッセージカウンタ
";
CM_ SG_ 1643 MCR66B_0_0_CHECK_SUM "チェックサム
";
CM_ SG_ 1642 MCR66A_7_0_CUR_POS_H_MIR_RMR "R鏡面：　現在位置H
";
CM_ SG_ 1642 MCR66A_5_0_CUR_POS_V_MIR_RMR "R鏡面：　現在位置V
";
CM_ SG_ 1642 MCR66A_3_0_STATE_ACT_MIR_RMR "R鏡面：　作動状態
";
CM_ SG_ 1642 MCR66A_2_0_CUR_POS_AFOLD_RMR "R電格：　現在位置
";
CM_ SG_ 1642 MCR66A_2_2_STATE_ACT_AFOLD_RMR "R電格：　作動状態
";
CM_ SG_ 1642 MCR66A_1_0_MSG_COUNTER "メッセージカウンタ
";
CM_ SG_ 1642 MCR66A_0_0_CHECK_SUM "チェックサム
";
CM_ SG_ 1665 CECU681_6_7_DP_CHANGE_SET_REQ "ドライバプロファイル設定変更要求フラグ
";
CM_ SG_ 1665 CECU681_6_4_SMT_LINK "スマート紐づけ
";
CM_ SG_ 1665 CECU681_6_3_IPMS_LINK "IPMS紐づけ
";
CM_ SG_ 1665 CECU681_5_6_DP_DKYMEM_LIST_NO15 "DriverProfileデジキー登録リストNo15
";
CM_ SG_ 1665 CECU681_5_5_DP_DKYMEM_LIST_NO14 "DriverProfileデジキー登録リストNo14
";
CM_ SG_ 1665 CECU681_5_4_DP_DKYMEM_LIST_NO13 "DriverProfileデジキー登録リストNo13
";
CM_ SG_ 1665 CECU681_5_3_DP_DKYMEM_LIST_NO12 "DriverProfileデジキー登録リストNo12
";
CM_ SG_ 1665 CECU681_5_2_DP_DKYMEM_LIST_NO11 "DriverProfileデジキー登録リストNo11
";
CM_ SG_ 1665 CECU681_5_1_DP_DKYMEM_LIST_NO10 "DriverProfileデジキー登録リストNo10
";
CM_ SG_ 1665 CECU681_5_0_DP_DKYMEM_LIST_NO9 "DriverProfileデジキー登録リストNo9
";
CM_ SG_ 1665 CECU681_4_7_DP_DKYMEM_LIST_NO8 "DriverProfileデジキー登録リストNo8
";
CM_ SG_ 1665 CECU681_4_6_DP_DKYMEM_LIST_NO7 "DriverProfileデジキー登録リストNo7
";
CM_ SG_ 1665 CECU681_4_5_DP_DKYMEM_LIST_NO6 "DriverProfileデジキー登録リストNo6
";
CM_ SG_ 1665 CECU681_4_4_DP_DKYMEM_LIST_NO5 "DriverProfileデジキー登録リストNo5
";
CM_ SG_ 1665 CECU681_4_3_DP_DKYMEM_LIST_NO4 "DriverProfileデジキー登録リストNo4
";
CM_ SG_ 1665 CECU681_4_2_DP_DKYMEM_LIST_NO3 "DriverProfileデジキー登録リストNo3
";
CM_ SG_ 1665 CECU681_4_1_DP_DKYMEM_LIST_NO2 "DriverProfileデジキー登録リストNo2
";
CM_ SG_ 1665 CECU681_4_0_DP_DKYMEM_LIST_NO1 "DriverProfileデジキー登録リストNo1
";
CM_ SG_ 1665 CECU681_3_5_RECOG_FACTOR "識別要因信号
";
CM_ SG_ 1665 CECU681_3_4_RECOG_USER_VALIDFRAG "識別ユーザ有効フラグ
";
CM_ SG_ 1665 CECU681_3_0_RESULT_NOTICE_REQ "処理結果表示要求
";
CM_ SG_ 1665 CECU681_2_4_RECOG_USER_NO "識別ユーザNo.
";
CM_ SG_ 1665 CECU681_2_0_POPUP_NOTICE_NO "ポップアップ表示ユーザNo.
";
CM_ SG_ 1665 CECU681_1_7_DP_FAILE_FRAG "DPフェールフラグ
";
CM_ SG_ 1665 CECU681_1_5_DP_PROCESS_RESULT "DP処理結果
";
CM_ SG_ 1665 CECU681_1_4_POPUP_NOTICE_REQ "ポップアップ表示要求
";
CM_ SG_ 1665 CECU681_1_0_MSG_COUNTER "メッセージカウンタ
";
CM_ SG_ 1665 CECU681_0_0_CHECK_SUM "ﾁｪｯｸｻﾑ
";
CM_ SG_ 1610 SMT64A_1_0_IADKCD "検証用SMTDKYコード
";
CM_ SG_ 1610 SMT64A_0_0_RGMDDK1 "デバイス登録要求１
";
CM_ SG_ 1605 SMT645_3_0_RQID2ME "イベント照合要求_照合スロット2_照合手段
";
CM_ SG_ 1605 SMT645_3_4_RQID2ID "イベント照合要求_照合スロット2_ID
";
CM_ SG_ 1605 SMT645_2_0_RQID2AR "イベント照合要求_照合スロット2_エリア
";
CM_ SG_ 1605 SMT645_2_4_RQID1ME "イベント照合要求_照合スロット1_照合手段
";
CM_ SG_ 1605 SMT645_1_0_RQID1ID "イベント照合要求_照合スロット1_ID
";
CM_ SG_ 1605 SMT645_1_4_RQID1AR "イベント照合要求_照合スロット1_エリア
";
CM_ SG_ 1605 SMT645_0_0_RQINF "イベント照合要求_照合レンジ
";
CM_ SG_ 1605 SMT645_0_2_RQIDCNT "イベント照合要求_カウンタ
";
CM_ SG_ 1605 SMT645_0_4_RQIDDEVI "イベント照合要求_デバイス指示
";
CM_ SG_ 1604 SMT644_6_0_RSPRECK "事前照合結果
";
CM_ SG_ 1604 SMT644_5_0_SPMODEID "照合ECU特殊モード中通知
";
CM_ SG_ 1604 SMT644_4_0_RSLT_OWCK "利用者認証結果
";
CM_ SG_ 1604 SMT644_3_0_OSSTARID "定期照合開始要求
";
CM_ SG_ 1604 SMT644_3_4_NUM_NFCCARD "NFCカード登録枚数
";
CM_ SG_ 1604 SMT644_2_0_RQISME "車室内照合要求_照合手段
";
CM_ SG_ 1604 SMT644_2_4_RQISDEVI "車室内照合要求_照合デバイス
";
CM_ SG_ 1604 SMT644_1_0_MSG_COUNTER "メッセージカウンタ
";
CM_ SG_ 1604 SMT644_0_0_CHECK_SUM "チェックサム
";
CM_ SG_ 1583 SMT62F_0_0_D_IADK4 "コード登録用データ4-1～4-8
";
CM_ SG_ 1582 SMT62E_0_0_D_IADK3 "コード登録用データ3-1～3-8
";
CM_ SG_ 1581 SMT62D_0_0_D_IADK2 "コード登録用データ2-1～2-8
";
CM_ SG_ 1580 SMT62C_0_0_D_IADK1 "コード登録用データ1-1～1-8
";
CM_ SG_ 1579 SMT62B_0_0_FVIADK1 "FV同期用応答データ
";
CM_ SG_ 1578 SMT62A_0_0_FVIADK1 "FV同期用要求データ
";
CM_ SG_ 1820 DKY71C_DIAG_DATA "ﾃﾞｰﾀ
";
CM_ SG_ 1812 CECU714_DIAG_DATA "ﾃﾞｰﾀ
";
CM_ SG_ 1313 DKY521_1_4_ActiveWakeUpBit "Active Wakeup ﾌﾗｸﾞ
";
CM_ SG_ 1313 DKY521_0_0_SourceNodeID "送信元ID
";
CM_ SG_ 1613 DKY64D_1_0_BLESRNO2 "デジタルキー制御ECUシリアルNo#2～8
";
CM_ SG_ 1613 DKY64D_0_0_BLESNO1 "デジタルキー制御ECUシリアルNo#1
";
CM_ SG_ 1613 DKY64D_0_5_BLEMSGID "シリアルNo送信ID
";
CM_ SG_ 1612 DKY64C_5_0_DKY_ID "新規登録KID
";
CM_ SG_ 1612 DKY64C_5_6_DKY_RSLT "デバイス登録応答状態
";
CM_ SG_ 1612 DKY64C_4_0_RSRGDK "デバイス登録応答
";
CM_ SG_ 1612 DKY64C_2_0_DKYSID "新規登録SlotIdentifier
";
CM_ SG_ 1612 DKY64C_0_0_DKRGNGFC "登録NG要因
";
CM_ SG_ 1609 DKY649_5_0_MACH2 "MAC値
";
CM_ SG_ 1609 DKY649_4_0_MACH1 "MAC値
";
CM_ SG_ 1609 DKY649_4_4_FVHRBL "Freshness Value
";
CM_ SG_ 1609 DKY649_3_0_TMIDH "デジタルキーID
";
CM_ SG_ 1609 DKY649_3_3_WCNTH "カウンタ値
";
CM_ SG_ 1609 DKY649_2_0_HWOPE2 "リモートコントロール操作指示内容2
";
CM_ SG_ 1609 DKY649_1_0_HWOPE1 "リモートコントロール操作指示内容1
";
CM_ SG_ 1609 DKY649_1_4_HWLOC "リモートコントロール操作対象機能
";
CM_ SG_ 1609 DKY649_0_4_KTYPEH "デジタルキー種別
";
CM_ SG_ 1608 DKY648_5_0_MACD2 "MAC値(下位24bit)
";
CM_ SG_ 1608 DKY648_4_0_MACD1 "MAC値(上位4bit)
";
CM_ SG_ 1608 DKY648_4_4_FVD "FV値
";
CM_ SG_ 1608 DKY648_3_0_TMIDD "デジタルキーID
";
CM_ SG_ 1608 DKY648_3_3_WCNTD "カウンタ値
";
CM_ SG_ 1608 DKY648_1_1_WINFD "リモートコントロール情報種別
";
CM_ SG_ 1608 DKY648_0_4_KTYPED "デジタルキー種別
";
CM_ SG_ 1607 DKY647_5_0_DKSENMC2 "MAC値(下位24bit)
";
CM_ SG_ 1607 DKY647_4_0_DKSENMC1 "MAC値(上位4bit)
";
CM_ SG_ 1607 DKY647_4_4_DKSENFV "FV値
";
CM_ SG_ 1607 DKY647_2_5_DKSEN1ME "ドアハンドルセンサ応答_照合スロット1_照合手段
";
CM_ SG_ 1607 DKY647_1_2_DKSEN1ID "ドアハンドルセンサ応答_照合スロット1_ID
";
CM_ SG_ 1607 DKY647_1_6_DKSEN1AR2 "ドアハンドルセンサ応答_照合スロット1_エリア(下位2bit)
";
CM_ SG_ 1607 DKY647_0_0_DKSEN1AR1 "ドアハンドルセンサ応答_照合スロット1_エリア(上位2bit)
";
CM_ SG_ 1607 DKY647_0_2_DKSENUNL "アンロックセンサ情報
";
CM_ SG_ 1607 DKY647_0_4_DKSENLOC "ロックセンサ情報
";
CM_ SG_ 1607 DKY647_0_6_DKSENCNT "センサカウンタ
";
CM_ SG_ 1737 DKY6C9_0_0_DKIACD "検証用DKYSMTコード
";
CM_ SG_ 1575 DKY627_6_0_SDRGT "スマートデバイス登録状態
";
CM_ SG_ 1575 DKY627_2_0_FRNDFDEOUT "フレンドデバイス猶予期間中
";
CM_ SG_ 1575 DKY627_0_5_SPNUM "スマートデバイス接続台数
";
CM_ SG_ 1574 DKY626_2_5_PS_OPSTD "節電状態
";
CM_ SG_ 1573 DKY625_0_6_DK_REGST "デジタルキー登録状態
";
CM_ SG_ 1571 DKY623_1_3_SPMDEDK "デジタルキーECU特殊モード中通知
";
CM_ SG_ 1571 DKY623_0_2_DKINDCST "デジタルキーカスタマイズ状態通知
";
CM_ SG_ 1571 DKY623_0_4_BZRQ_DK "発信機ダイアグブザー吹鳴要求
";
CM_ SG_ 1565 DKY61D_0_0_D_DKIA7 "コード登録用データ7-1～7-8
";
CM_ SG_ 1564 DKY61C_0_0_D_DKIA6 "コード登録用データ6-1～6-8
";
CM_ SG_ 1563 DKY61B_0_0_D_DKIA5 "コード登録用データ5-1～5-8
";
CM_ SG_ 1562 DKY61A_0_0_D_DKIA4 "コード登録用データ4-1～4-8
";
CM_ SG_ 1561 DKY619_0_0_D_DKIA3 "コード登録用データ3-1～3-8
";
CM_ SG_ 1560 DKY618_0_0_D_DKIA2 "コード登録用データ2-1～2-8
";
CM_ SG_ 1559 DKY617_0_0_D_DKIA1 "コード登録用データ1-1～1-8
";
CM_ SG_ 1558 DKY616_0_0_FVDKIA1 "FV同期用応答データ
";
CM_ SG_ 1557 DKY615_0_0_FVDKIA0 "FV同期用要求データ
";
CM_ SG_ 1556 DKY614_5_0_RSDKMC2 "MAC値
";
CM_ SG_ 1556 DKY614_4_0_RSDKMC1 "MAC値
";
CM_ SG_ 1556 DKY614_4_4_RSDKFV "Freshness Value
";
CM_ SG_ 1556 DKY614_3_0_RSDK2ME "イベント照合結果_照合スロット2_照合デバイス
";
CM_ SG_ 1556 DKY614_3_5_RSDK2ID2 "イベント照合結果_照合スロット2_キーID
";
CM_ SG_ 1556 DKY614_2_0_RSDK2ID1 "イベント照合結果_照合スロット2_キーID
";
CM_ SG_ 1556 DKY614_2_1_RSDK2SAR "イベント照合結果_照合スロット2_エリア
";
CM_ SG_ 1556 DKY614_2_5_RSDK1ME "イベント照合結果_照合スロット1_照合デバイス
";
CM_ SG_ 1556 DKY614_1_2_RSDK1ID "イベント照合結果_照合スロット１_キーID
";
CM_ SG_ 1556 DKY614_1_6_RSDK1AR2 "イベント照合結果_照合スロット1_エリア
";
CM_ SG_ 1556 DKY614_0_0_RSDK1AR1 "イベント照合結果_照合スロット1_エリア
";
CM_ SG_ 1556 DKY614_0_2_RSDKNF "イベント照合結果_照合レンジ
";
CM_ SG_ 1556 DKY614_0_4_RSDKCNT "イベント照合結果_カウンタ
";
CM_ SG_ 1556 DKY614_0_6_RSDKIDTS "イベント照合結果_ステータス
";
CM_ SG_ 1555 DKY613_5_0_OSDKMC2 "MAC値
";
CM_ SG_ 1555 DKY613_4_0_OSDKMC1 "MAC値
";
CM_ SG_ 1555 DKY613_4_4_OSDKFV "Freshness Value
";
CM_ SG_ 1555 DKY613_3_2_OSDKFRID "車室外照合結果_Fr_ID
";
CM_ SG_ 1555 DKY613_3_6_OSDKFRNF "車室外照合結果_Fr_照合レンジ
";
CM_ SG_ 1555 DKY_613_1_1_OSDKRRID "車室外照合結果_ラゲージ外_ID
";
CM_ SG_ 1555 DKY613_1_5_OSKYRRNF "車室外照合結果_ラゲージ外_照合レンジ
";
CM_ SG_ 1555 DKY613_1_6_OSDKPID2 "車室外照合結果_P席_ID
";
CM_ SG_ 1555 DKY613_0_0_OSDKPID1 "車室外照合結果_P席_ID
";
CM_ SG_ 1555 DKY613_0_2_OSDKPNF "車室外照合結果_P席_照合レンジ
";
CM_ SG_ 1555 DKY613_0_3_OSDKDID "車室外照合結果_D席_ID
";
CM_ SG_ 1555 DKY613_0_7_OSDKDNF "車室外照合結果_D席_照合レンジ
";
CM_ SG_ 1554 DKY612_5_0_RSISDKMC2 "MAC値
";
CM_ SG_ 1554 DKY612_4_0_RSISDKMC1 "MAC値
";
CM_ SG_ 1554 DKY612_4_4_RSISDKFV "Freshness Value
";
CM_ SG_ 1554 DKY612_0_1_RSISDDK "車室内照合結果_照合結果
";
CM_ SG_ 1554 DKY612_0_6_RSISDKME "車室内照合結果_照合デバイス
";
BA_DEF_ SG_  "Fhi_SignalComment" STRING ;
BA_DEF_ SG_  "GenSigInactiveValue" INT 0 10000;
BA_DEF_ SG_  "GenSigStartValue" FLOAT 0 100000000000;
BA_DEF_ SG_  "GenSigSendType" ENUM  "Cyclic","OnWrite","OnWriteWithRepetition","OnChange","OnChangeWithRepetition","IfActive","IfActiveWithRepetition","NoSigSendType";
BA_DEF_ BO_  "MsgRoutingId" STRING ;
BA_DEF_ BO_  "DiagResponse" ENUM  "No","Yes";
BA_DEF_ BO_  "DiagRequest" ENUM  "No","Yes";
BA_DEF_ BO_  "DiagState" ENUM  "No","Yes";
BA_DEF_ BO_  "GenMsgILSupport" ENUM  "No","Yes";
BA_DEF_ BO_  "GenMsgNrOfRepetition" INT 0 999999;
BA_DEF_ BO_  "GenMsgDelayTime" INT 0 1000;
BA_DEF_ BO_  "GenMsgCycleTimeFast" INT 0 10000;
BA_DEF_ BO_  "GenMsgCycleTime" INT 0 10000;
BA_DEF_ BO_  "GenMsgSendType" ENUM  "Cyclic","NotUsed","NotUsed","NotUsed","NotUsed","Cyclic","NotUsed","IfActive","NoMsgSendType";
BA_DEF_DEF_  "Fhi_SignalComment" "";
BA_DEF_DEF_  "GenSigInactiveValue" 0;
BA_DEF_DEF_  "GenSigStartValue" 0;
BA_DEF_DEF_  "GenSigSendType" "NoSigSendType";
BA_DEF_DEF_  "MsgRoutingId" "";
BA_DEF_DEF_  "DiagResponse" "No";
BA_DEF_DEF_  "DiagRequest" "No";
BA_DEF_DEF_  "DiagState" "No";
BA_DEF_DEF_  "GenMsgILSupport" "Yes";
BA_DEF_DEF_  "GenMsgNrOfRepetition" 0;
BA_DEF_DEF_  "GenMsgDelayTime" 0;
BA_DEF_DEF_  "GenMsgCycleTimeFast" 0;
BA_DEF_DEF_  "GenMsgCycleTime" 0;
BA_DEF_DEF_  "GenMsgSendType" "Cyclic";
BA_ "GenMsgCycleTime" BO_ 948 100;
BA_ "GenMsgDelayTime" BO_ 948 10;
BA_ "MsgRoutingId" BO_ 948 "78 ";
BA_ "GenMsgCycleTime" BO_ 1005 500;
BA_ "GenMsgDelayTime" BO_ 1005 10;
BA_ "GenMsgCycleTimeFast" BO_ 1005 20;
BA_ "GenMsgNrOfRepetition" BO_ 1005 3;
BA_ "MsgRoutingId" BO_ 1005 "76 ";
BA_ "GenMsgILSupport" BO_ 1005 0;
BA_ "GenMsgCycleTime" BO_ 1723 1200;
BA_ "GenMsgDelayTime" BO_ 1723 10;
BA_ "GenMsgCycleTimeFast" BO_ 1723 50;
BA_ "GenMsgNrOfRepetition" BO_ 1723 4;
BA_ "MsgRoutingId" BO_ 1723 "72 ";
BA_ "GenMsgILSupport" BO_ 1723 0;
BA_ "GenMsgDelayTime" BO_ 1722 10;
BA_ "GenMsgSendType" BO_ 1722 8;
BA_ "GenMsgCycleTimeFast" BO_ 1722 20;
BA_ "GenMsgNrOfRepetition" BO_ 1722 3;
BA_ "MsgRoutingId" BO_ 1722 "71 ";
BA_ "GenMsgILSupport" BO_ 1722 0;
BA_ "GenMsgCycleTime" BO_ 1019 500;
BA_ "GenMsgDelayTime" BO_ 1019 10;
BA_ "GenMsgCycleTimeFast" BO_ 1019 20;
BA_ "GenMsgNrOfRepetition" BO_ 1019 3;
BA_ "MsgRoutingId" BO_ 1019 "69 ";
BA_ "GenMsgILSupport" BO_ 1019 0;
BA_ "GenMsgDelayTime" BO_ 1767 10;
BA_ "GenMsgSendType" BO_ 1767 8;
BA_ "GenMsgCycleTimeFast" BO_ 1767 20;
BA_ "GenMsgNrOfRepetition" BO_ 1767 1;
BA_ "MsgRoutingId" BO_ 1767 "68 ";
BA_ "GenMsgILSupport" BO_ 1767 0;
BA_ "GenMsgCycleTime" BO_ 1765 1200;
BA_ "GenMsgDelayTime" BO_ 1765 10;
BA_ "MsgRoutingId" BO_ 1765 "67 ";
BA_ "GenMsgILSupport" BO_ 1765 0;
BA_ "GenMsgCycleTime" BO_ 1635 1000;
BA_ "MsgRoutingId" BO_ 1635 "65 ";
BA_ "GenMsgCycleTime" BO_ 985 200;
BA_ "MsgRoutingId" BO_ 985 "64 ";
BA_ "GenMsgCycleTime" BO_ 1363 1000;
BA_ "GenMsgDelayTime" BO_ 1631 10;
BA_ "GenMsgSendType" BO_ 1631 8;
BA_ "GenMsgCycleTimeFast" BO_ 1631 20;
BA_ "GenMsgNrOfRepetition" BO_ 1631 1;
BA_ "MsgRoutingId" BO_ 1631 "63 ";
BA_ "GenMsgCycleTime" BO_ 1296 1000;
BA_ "GenMsgCycleTime" BO_ 1639 1200;
BA_ "GenMsgDelayTime" BO_ 1639 10;
BA_ "GenMsgCycleTimeFast" BO_ 1639 120;
BA_ "GenMsgNrOfRepetition" BO_ 1639 3;
BA_ "GenMsgCycleTime" BO_ 1638 1200;
BA_ "GenMsgDelayTime" BO_ 1638 10;
BA_ "GenMsgCycleTimeFast" BO_ 1638 120;
BA_ "GenMsgNrOfRepetition" BO_ 1638 3;
BA_ "GenMsgCycleTime" BO_ 1624 1200;
BA_ "GenMsgDelayTime" BO_ 1624 10;
BA_ "GenMsgCycleTimeFast" BO_ 1624 120;
BA_ "GenMsgNrOfRepetition" BO_ 1624 3;
BA_ "GenMsgCycleTime" BO_ 1623 1200;
BA_ "GenMsgDelayTime" BO_ 1623 10;
BA_ "GenMsgCycleTimeFast" BO_ 1623 120;
BA_ "GenMsgNrOfRepetition" BO_ 1623 3;
BA_ "GenMsgCycleTime" BO_ 1661 1200;
BA_ "GenMsgDelayTime" BO_ 1661 15;
BA_ "GenMsgCycleTimeFast" BO_ 1661 120;
BA_ "GenMsgNrOfRepetition" BO_ 1661 4;
BA_ "GenMsgCycleTime" BO_ 1298 1000;
BA_ "GenMsgCycleTime" BO_ 1662 1200;
BA_ "GenMsgDelayTime" BO_ 1662 15;
BA_ "GenMsgCycleTimeFast" BO_ 1662 120;
BA_ "GenMsgNrOfRepetition" BO_ 1662 4;
BA_ "GenMsgCycleTime" BO_ 1297 1000;
BA_ "GenMsgCycleTime" BO_ 1645 1000;
BA_ "GenMsgDelayTime" BO_ 1645 10;
BA_ "GenMsgNrOfRepetition" BO_ 1645 1;
BA_ "GenMsgCycleTime" BO_ 1294 1000;
BA_ "GenMsgCycleTime" BO_ 1646 1000;
BA_ "GenMsgDelayTime" BO_ 1646 10;
BA_ "GenMsgNrOfRepetition" BO_ 1646 1;
BA_ "MsgRoutingId" BO_ 1646 "62 ";
BA_ "GenMsgCycleTime" BO_ 1628 1000;
BA_ "GenMsgDelayTime" BO_ 1628 10;
BA_ "GenMsgNrOfRepetition" BO_ 1628 1;
BA_ "GenMsgCycleTime" BO_ 818 120;
BA_ "GenMsgDelayTime" BO_ 818 10;
BA_ "GenMsgNrOfRepetition" BO_ 818 1;
BA_ "MsgRoutingId" BO_ 818 "61 ";
BA_ "GenMsgCycleTime" BO_ 1303 1000;
BA_ "GenMsgDelayTime" BO_ 1603 10;
BA_ "GenMsgSendType" BO_ 1603 8;
BA_ "GenMsgCycleTimeFast" BO_ 1603 20;
BA_ "GenMsgNrOfRepetition" BO_ 1603 1;
BA_ "MsgRoutingId" BO_ 1603 "60 ";
BA_ "GenMsgDelayTime" BO_ 1601 10;
BA_ "GenMsgSendType" BO_ 1601 8;
BA_ "GenMsgCycleTimeFast" BO_ 1601 50;
BA_ "GenMsgNrOfRepetition" BO_ 1601 1;
BA_ "MsgRoutingId" BO_ 1601 "59 ";
BA_ "GenMsgCycleTime" BO_ 1600 1200;
BA_ "GenMsgDelayTime" BO_ 1600 10;
BA_ "MsgRoutingId" BO_ 1600 "58 ";
BA_ "GenMsgCycleTime" BO_ 816 120;
BA_ "GenMsgDelayTime" BO_ 816 10;
BA_ "MsgRoutingId" BO_ 816 "57 ";
BA_ "GenMsgCycleTime" BO_ 1289 1000;
BA_ "GenMsgCycleTime" BO_ 1759 1200;
BA_ "GenMsgDelayTime" BO_ 1759 10;
BA_ "GenMsgCycleTime" BO_ 1622 1000;
BA_ "GenMsgDelayTime" BO_ 1622 10;
BA_ "GenMsgCycleTimeFast" BO_ 1622 20;
BA_ "GenMsgNrOfRepetition" BO_ 1622 10;
BA_ "MsgRoutingId" BO_ 1622 "56 ";
BA_ "GenMsgCycleTime" BO_ 1621 1000;
BA_ "GenMsgDelayTime" BO_ 1621 10;
BA_ "GenMsgCycleTimeFast" BO_ 1621 20;
BA_ "GenMsgNrOfRepetition" BO_ 1621 10;
BA_ "MsgRoutingId" BO_ 1621 "55 ";
BA_ "GenMsgCycleTime" BO_ 1620 1200;
BA_ "GenMsgDelayTime" BO_ 1620 10;
BA_ "MsgRoutingId" BO_ 1620 "54 ";
BA_ "GenMsgCycleTime" BO_ 1618 1200;
BA_ "GenMsgDelayTime" BO_ 1618 10;
BA_ "MsgRoutingId" BO_ 1618 "53 ";
BA_ "GenMsgCycleTime" BO_ 1617 1200;
BA_ "GenMsgDelayTime" BO_ 1617 10;
BA_ "MsgRoutingId" BO_ 1617 "52 ";
BA_ "GenMsgCycleTime" BO_ 995 200;
BA_ "MsgRoutingId" BO_ 995 "51 ";
BA_ "GenMsgCycleTime" BO_ 994 200;
BA_ "GenMsgCycleTime" BO_ 942 100;
BA_ "GenMsgDelayTime" BO_ 942 10;
BA_ "GenMsgCycleTimeFast" BO_ 942 20;
BA_ "GenMsgNrOfRepetition" BO_ 942 2;
BA_ "MsgRoutingId" BO_ 942 "50 ";
BA_ "GenMsgCycleTime" BO_ 940 100;
BA_ "GenMsgDelayTime" BO_ 940 10;
BA_ "GenMsgCycleTimeFast" BO_ 940 20;
BA_ "GenMsgNrOfRepetition" BO_ 940 10;
BA_ "MsgRoutingId" BO_ 940 "49 ";
BA_ "GenMsgCycleTime" BO_ 1286 1000;
BA_ "GenMsgCycleTime" BO_ 960 100;
BA_ "GenMsgDelayTime" BO_ 960 10;
BA_ "GenMsgCycleTimeFast" BO_ 960 20;
BA_ "GenMsgNrOfRepetition" BO_ 960 10;
BA_ "MsgRoutingId" BO_ 960 "48 ";
BA_ "GenMsgCycleTime" BO_ 1616 1000;
BA_ "GenMsgDelayTime" BO_ 1616 10;
BA_ "GenMsgCycleTimeFast" BO_ 1616 20;
BA_ "GenMsgNrOfRepetition" BO_ 1616 10;
BA_ "MsgRoutingId" BO_ 1616 "47 ";
BA_ "GenMsgCycleTime" BO_ 1615 1000;
BA_ "GenMsgDelayTime" BO_ 1615 10;
BA_ "GenMsgCycleTimeFast" BO_ 1615 20;
BA_ "GenMsgNrOfRepetition" BO_ 1615 10;
BA_ "MsgRoutingId" BO_ 1615 "46 ";
BA_ "GenMsgCycleTime" BO_ 859 100;
BA_ "MsgRoutingId" BO_ 859 "42 ";
BA_ "GenMsgCycleTime" BO_ 1368 1000;
BA_ "GenMsgCycleTime" BO_ 811 100;
BA_ "GenMsgDelayTime" BO_ 811 10;
BA_ "MsgRoutingId" BO_ 811 "40 ";
BA_ "GenMsgILSupport" BO_ 811 0;
BA_ "GenMsgCycleTime" BO_ 323 20;
BA_ "MsgRoutingId" BO_ 323 "39 ";
BA_ "GenMsgILSupport" BO_ 323 0;
BA_ "GenMsgCycleTime" BO_ 362 20;
BA_ "MsgRoutingId" BO_ 362 "38 ";
BA_ "GenMsgILSupport" BO_ 362 0;
BA_ "GenMsgCycleTime" BO_ 316 20;
BA_ "MsgRoutingId" BO_ 316 "36 ";
BA_ "GenMsgILSupport" BO_ 316 0;
BA_ "GenMsgCycleTime" BO_ 315 20;
BA_ "MsgRoutingId" BO_ 315 "35 ";
BA_ "GenMsgILSupport" BO_ 315 0;
BA_ "GenMsgCycleTime" BO_ 313 20;
BA_ "MsgRoutingId" BO_ 313 "33 ";
BA_ "GenMsgILSupport" BO_ 313 0;
BA_ "GenMsgCycleTime" BO_ 312 20;
BA_ "MsgRoutingId" BO_ 312 "32 ";
BA_ "GenMsgILSupport" BO_ 312 0;
BA_ "GenMsgCycleTime" BO_ 946 120;
BA_ "GenMsgCycleTimeFast" BO_ 946 50;
BA_ "GenMsgNrOfRepetition" BO_ 946 3;
BA_ "MsgRoutingId" BO_ 946 "30 ";
BA_ "GenMsgILSupport" BO_ 946 0;
BA_ "GenMsgCycleTime" BO_ 952 500;
BA_ "MsgRoutingId" BO_ 952 "29 ";
BA_ "GenMsgILSupport" BO_ 952 0;
BA_ "GenMsgCycleTime" BO_ 1710 1200;
BA_ "GenMsgDelayTime" BO_ 1710 10;
BA_ "GenMsgCycleTimeFast" BO_ 1710 50;
BA_ "GenMsgNrOfRepetition" BO_ 1710 4;
BA_ "MsgRoutingId" BO_ 1710 "26 ";
BA_ "GenMsgILSupport" BO_ 1710 0;
BA_ "GenMsgCycleTime" BO_ 1707 1200;
BA_ "GenMsgDelayTime" BO_ 1707 10;
BA_ "GenMsgCycleTimeFast" BO_ 1707 50;
BA_ "GenMsgNrOfRepetition" BO_ 1707 4;
BA_ "MsgRoutingId" BO_ 1707 "23 ";
BA_ "GenMsgILSupport" BO_ 1707 0;
BA_ "GenMsgCycleTime" BO_ 1706 1200;
BA_ "GenMsgDelayTime" BO_ 1706 10;
BA_ "GenMsgCycleTimeFast" BO_ 1706 50;
BA_ "GenMsgNrOfRepetition" BO_ 1706 4;
BA_ "MsgRoutingId" BO_ 1706 "22 ";
BA_ "GenMsgILSupport" BO_ 1706 0;
BA_ "GenMsgCycleTime" BO_ 1704 1200;
BA_ "GenMsgDelayTime" BO_ 1704 10;
BA_ "GenMsgCycleTimeFast" BO_ 1704 50;
BA_ "GenMsgNrOfRepetition" BO_ 1704 4;
BA_ "MsgRoutingId" BO_ 1704 "21 ";
BA_ "GenMsgILSupport" BO_ 1704 0;
BA_ "GenMsgCycleTime" BO_ 1649 1200;
BA_ "GenMsgDelayTime" BO_ 1649 10;
BA_ "GenMsgCycleTimeFast" BO_ 1649 120;
BA_ "GenMsgNrOfRepetition" BO_ 1649 3;
BA_ "GenMsgCycleTime" BO_ 1648 1200;
BA_ "GenMsgDelayTime" BO_ 1648 10;
BA_ "GenMsgCycleTimeFast" BO_ 1648 120;
BA_ "GenMsgNrOfRepetition" BO_ 1648 3;
BA_ "GenMsgCycleTime" BO_ 1647 1200;
BA_ "GenMsgDelayTime" BO_ 1647 10;
BA_ "GenMsgCycleTimeFast" BO_ 1647 120;
BA_ "GenMsgNrOfRepetition" BO_ 1647 3;
BA_ "GenMsgCycleTime" BO_ 1644 1200;
BA_ "GenMsgDelayTime" BO_ 1644 10;
BA_ "GenMsgCycleTimeFast" BO_ 1644 120;
BA_ "GenMsgNrOfRepetition" BO_ 1644 3;
BA_ "GenMsgCycleTime" BO_ 1643 1200;
BA_ "GenMsgDelayTime" BO_ 1643 10;
BA_ "GenMsgCycleTimeFast" BO_ 1643 120;
BA_ "GenMsgNrOfRepetition" BO_ 1643 3;
BA_ "GenMsgCycleTime" BO_ 1642 1200;
BA_ "GenMsgDelayTime" BO_ 1642 10;
BA_ "GenMsgCycleTimeFast" BO_ 1642 120;
BA_ "GenMsgNrOfRepetition" BO_ 1642 3;
BA_ "GenMsgSendType" BO_ 1808 8;
BA_ "MsgRoutingId" BO_ 1808 "9 ";
BA_ "GenMsgILSupport" BO_ 1808 0;
BA_ "GenMsgCycleTime" BO_ 992 500;
BA_ "GenMsgCycleTime" BO_ 1665 1000;
BA_ "GenMsgSendType" BO_ 1610 8;
BA_ "GenMsgNrOfRepetition" BO_ 1610 1;
BA_ "GenMsgSendType" BO_ 1605 8;
BA_ "GenMsgCycleTime" BO_ 1604 1000;
BA_ "GenMsgNrOfRepetition" BO_ 1604 1;
BA_ "GenMsgSendType" BO_ 1583 8;
BA_ "GenMsgSendType" BO_ 1582 8;
BA_ "GenMsgSendType" BO_ 1581 8;
BA_ "GenMsgSendType" BO_ 1580 8;
BA_ "GenMsgSendType" BO_ 1579 8;
BA_ "GenMsgSendType" BO_ 1578 8;
BA_ "GenMsgSendType" BO_ 1816 8;
BA_ "MsgRoutingId" BO_ 1816 "7 ";
BA_ "GenMsgSendType" BO_ 1820 8;
BA_ "GenMsgNrOfRepetition" BO_ 1820 1;
BA_ "DiagResponse" BO_ 1820 1;
BA_ "GenMsgILSupport" BO_ 1820 0;
BA_ "GenMsgSendType" BO_ 1812 8;
BA_ "GenMsgNrOfRepetition" BO_ 1812 1;
BA_ "DiagRequest" BO_ 1812 1;
BA_ "GenMsgILSupport" BO_ 1812 0;
BA_ "GenMsgCycleTime" BO_ 1313 1000;
BA_ "GenMsgSendType" BO_ 1613 8;
BA_ "MsgRoutingId" BO_ 1613 "6 ";
BA_ "GenMsgSendType" BO_ 1612 8;
BA_ "GenMsgNrOfRepetition" BO_ 1612 1;
BA_ "MsgRoutingId" BO_ 1612 "5 ";
BA_ "GenMsgSendType" BO_ 1609 8;
BA_ "GenMsgCycleTime" BO_ 1608 1000;
BA_ "GenMsgDelayTime" BO_ 1608 10;
BA_ "GenMsgNrOfRepetition" BO_ 1608 1;
BA_ "MsgRoutingId" BO_ 1608 "4 ";
BA_ "GenMsgCycleTime" BO_ 982 120;
BA_ "MsgRoutingId" BO_ 982 "3 ";
BA_ "GenMsgCycleTime" BO_ 1013 500;
BA_ "GenMsgSendType" BO_ 1607 8;
BA_ "GenMsgNrOfRepetition" BO_ 1607 1;
BA_ "GenMsgSendType" BO_ 1737 8;
BA_ "GenMsgNrOfRepetition" BO_ 1737 1;
BA_ "GenMsgCycleTime" BO_ 1575 1000;
BA_ "GenMsgNrOfRepetition" BO_ 1575 1;
BA_ "MsgRoutingId" BO_ 1575 "2 ";
BA_ "GenMsgCycleTime" BO_ 1574 1000;
BA_ "GenMsgNrOfRepetition" BO_ 1574 1;
BA_ "GenMsgCycleTime" BO_ 1573 1000;
BA_ "GenMsgNrOfRepetition" BO_ 1573 1;
BA_ "GenMsgCycleTime" BO_ 1571 1000;
BA_ "GenMsgNrOfRepetition" BO_ 1571 1;
BA_ "GenMsgCycleTime" BO_ 1565 1000;
BA_ "GenMsgNrOfRepetition" BO_ 1565 1;
BA_ "GenMsgCycleTime" BO_ 1564 1000;
BA_ "GenMsgNrOfRepetition" BO_ 1564 1;
BA_ "GenMsgCycleTime" BO_ 1563 1000;
BA_ "GenMsgNrOfRepetition" BO_ 1563 1;
BA_ "GenMsgCycleTime" BO_ 1562 1000;
BA_ "GenMsgNrOfRepetition" BO_ 1562 1;
BA_ "GenMsgSendType" BO_ 1561 8;
BA_ "GenMsgNrOfRepetition" BO_ 1561 1;
BA_ "GenMsgSendType" BO_ 1560 8;
BA_ "GenMsgNrOfRepetition" BO_ 1560 1;
BA_ "GenMsgSendType" BO_ 1559 8;
BA_ "GenMsgNrOfRepetition" BO_ 1559 1;
BA_ "GenMsgSendType" BO_ 1558 8;
BA_ "GenMsgSendType" BO_ 1557 8;
BA_ "GenMsgSendType" BO_ 1556 8;
BA_ "GenMsgNrOfRepetition" BO_ 1556 1;
BA_ "GenMsgSendType" BO_ 1555 8;
BA_ "GenMsgNrOfRepetition" BO_ 1555 1;
BA_ "GenMsgSendType" BO_ 1554 8;
BA_ "GenMsgCycleTimeFast" BO_ 1554 750;
BA_ "GenMsgNrOfRepetition" BO_ 1554 1;
BA_ "GenSigStartValue" SG_ 948 ACN3B4_2_0_AMB_AC 8191;
BA_ "GenSigStartValue" SG_ 1723 AVN6BB_7_0_ISA_IACC_OFFSET_CSTM 10;
BA_ "GenSigSendType" SG_ 1722 AVN6BA_7_0_GUIDE_LINE_REAR 4;
BA_ "GenSigSendType" SG_ 1722 AVN6BA_7_1_GUIDE_LINE_SIDE 4;
BA_ "GenSigSendType" SG_ 1722 AVN6BA_7_2_GUIDE_LINE_FRONT 4;
BA_ "GenSigSendType" SG_ 1722 AVN6BA_7_3_STEER_ANGLE_INTERLOCK 4;
BA_ "GenSigSendType" SG_ 1722 AVN6BA_7_4_BACK_CAMERA_DELAY 4;
BA_ "GenSigSendType" SG_ 1722 AVN6BA_7_5_REQ_STOP_CAMERA_OUT 4;
BA_ "GenSigSendType" SG_ 1722 AVN6BA_7_6_VIEW_CHANGE_SW 4;
BA_ "GenSigStartValue" SG_ 1722 AVN6BA_6_0_CLIMAITE_PA_TEMP 63;
BA_ "Fhi_SignalComment" SG_ 1722 AVN6BA_6_0_CLIMAITE_PA_TEMP "分解能、ｵﾌｾｯﾄは摂氏時の値。華氏の場合はﾃﾞｰﾀｼｰﾄ参照。

";
BA_ "GenSigSendType" SG_ 1722 AVN6BA_6_0_CLIMAITE_PA_TEMP 4;
BA_ "GenSigSendType" SG_ 1722 AVN6BA_6_6_CLIMATE_SYNC 4;
BA_ "GenSigSendType" SG_ 1722 AVN6BA_6_7_CLIMATE_F_DEF 4;
BA_ "Fhi_SignalComment" SG_ 1722 AVN6BA_5_0_CLIMAITE_DR_TEMP "分解能、ｵﾌｾｯﾄは摂氏時の値。華氏の場合はﾃﾞｰﾀｼｰﾄ参照。

";
BA_ "GenSigSendType" SG_ 1722 AVN6BA_5_0_CLIMAITE_DR_TEMP 4;
BA_ "GenSigSendType" SG_ 1722 AVN6BA_5_6_CLIMAITE_AUTO 4;
BA_ "GenSigSendType" SG_ 1722 AVN6BA_5_7_CLIMAITE_MAX_AC 4;
BA_ "GenSigSendType" SG_ 1722 AVN6BA_4_0_CLIMAITE_VR 4;
BA_ "GenSigSendType" SG_ 1722 AVN6BA_4_3_CLIMATE_AC 4;
BA_ "GenSigSendType" SG_ 1722 AVN6BA_4_4_CLIMAITE_FAN 4;
BA_ "GenSigSendType" SG_ 1722 AVN6BA_3_0_PERSONAL_IC_SH 4;
BA_ "GenSigSendType" SG_ 1722 AVN6BA_3_4_CSTM_SONNER 4;
BA_ "GenSigSendType" SG_ 1722 AVN6BA_3_5_CSTM_RAB 4;
BA_ "GenSigSendType" SG_ 1722 AVN6BA_3_6_REQ_CHG_CSTM_RAB 4;
BA_ "GenSigSendType" SG_ 1722 AVN6BA_3_7_CLIMATE_R_DEF 4;
BA_ "GenSigSendType" SG_ 1722 AVN6BA_2_0_CLIMATE_PTC 4;
BA_ "GenSigSendType" SG_ 1722 AVN6BA_2_1_CLIMATE_MODE 4;
BA_ "GenSigSendType" SG_ 1722 AVN6BA_2_2_CLIMATE_SEAT_C_L 4;
BA_ "GenSigSendType" SG_ 1722 AVN6BA_2_3_CLIMATE_SEAT_C_R 4;
BA_ "GenSigSendType" SG_ 1722 AVN6BA_2_4_CLIMATE_SEAT_H_L 4;
BA_ "GenSigSendType" SG_ 1722 AVN6BA_2_5_CLIMATE_SEAT_H_R 4;
BA_ "GenSigSendType" SG_ 1722 AVN6BA_2_6_CLIMATE_INNER_AIR 4;
BA_ "GenSigSendType" SG_ 1722 AVN6BA_2_7_CLIMATE_ON_OFF 4;
BA_ "GenSigSendType" SG_ 1722 AVN6BA_1_4_CLIMAITE_STATUS 4;
BA_ "GenSigSendType" SG_ 1722 AVN6BA_1_7_CLIMAITE_ON_OFF 4;
BA_ "GenSigStartValue" SG_ 1019 AVN3FB_6_0_ACPANEL_PA_TEMP 63;
BA_ "GenSigStartValue" SG_ 1019 AVN3FB_5_0_ACPANEL_DR_TEMP 63;
BA_ "GenSigSendType" SG_ 1767 RES6E7_2_0_DATA2 4;
BA_ "GenSigSendType" SG_ 1767 RES6E7_1_4_DATA1 4;
BA_ "GenSigSendType" SG_ 1765 RES6E5_6_0_REQ_DOOR_LOCK_ARM 3;
BA_ "GenSigSendType" SG_ 1765 RES6E5_6_3_ON_SIGN 3;
BA_ "GenSigStartValue" SG_ 1635 AHL663_2_0_FAIL_AHL 4;
BA_ "GenSigStartValue" SG_ 985 AHL3D9_3_0_ROLL_ANGLE 255;
BA_ "GenSigStartValue" SG_ 985 AHL3D9_2_0_PITCH_ANGLE 255;
BA_ "GenSigSendType" SG_ 1631 IMB65F_2_0_DATA2 4;
BA_ "GenSigSendType" SG_ 1631 IMB65F_1_4_DATA1 4;
BA_ "GenSigStartValue" SG_ 1624 PSC658_7_0_CUR_POS_TLT 65535;
BA_ "GenSigStartValue" SG_ 1624 PSC658_4_0_CUR_POS_LFT 65535;
BA_ "GenSigStartValue" SG_ 1623 PSC657_7_0_CUR_POS_RCL 65535;
BA_ "GenSigStartValue" SG_ 1623 PSC657_4_0_CUR_POS_SLD 65535;
BA_ "GenSigSendType" SG_ 1645 PRG66D_4_0_BUZZER_RQ_PRG 3;
BA_ "GenSigSendType" SG_ 1645 PRG66D_4_7_PRG_HF_ON_OFF 3;
BA_ "GenSigSendType" SG_ 1645 PRG66D_3_1_PRG_MEMORY_ON_OFF 3;
BA_ "GenSigSendType" SG_ 1645 PRG66D_3_3_PRG_LOCK_SW_RQ 3;
BA_ "GenSigSendType" SG_ 1645 PRG66D_3_5_KICK_CSTM_TIMER 3;
BA_ "GenSigSendType" SG_ 1645 PRG66D_2_2_HAZARD 3;
BA_ "GenSigSendType" SG_ 1646 PRG66E_7_0_FACT_PRG_REFUSE_FAIL 3;
BA_ "GenSigSendType" SG_ 1646 PRG66E_6_0_FACT_PRG_REFUSE 3;
BA_ "GenSigSendType" SG_ 1646 PRG66E_5_5_PERMIT_PRG_OPER 3;
BA_ "GenSigSendType" SG_ 1646 PRG66E_4_0_PERM_PRG_OPER_OPEN 3;
BA_ "GenSigSendType" SG_ 1646 PRG66E_4_1_PERM_PRG_OPER_OPEN 3;
BA_ "GenSigSendType" SG_ 1646 PRG66E_4_2_FACT_PRG_OPER 3;
BA_ "GenSigSendType" SG_ 1646 PRG66E_4_6_CUR_RG_STATE 3;
BA_ "GenSigSendType" SG_ 1646 PRG66E_2_4_SW_PRG_PULS_CLOSE 3;
BA_ "GenSigSendType" SG_ 1646 PRG66E_2_5_SW_PRG_PULS_OPEN 3;
BA_ "GenSigSendType" SG_ 1646 PRG66E_2_6_SW_PRG_LOCK 3;
BA_ "GenSigSendType" SG_ 1646 PRG66E_2_7_SW_PRG_INNER 3;
BA_ "GenSigStartValue" SG_ 1646 PRG66E_1_4_STATUS_PRG_OPER 5;
BA_ "GenSigSendType" SG_ 1646 PRG66E_1_4_STATUS_PRG_OPER 3;
BA_ "GenSigSendType" SG_ 1646 PRG66E_1_7_PERMIT_MEM_POS_PRG 3;
BA_ "GenSigSendType" SG_ 1628 PRG65C_3_0_FLAG_PRG_FAIL_B 3;
BA_ "GenSigSendType" SG_ 1628 PRG65C_2_0_FLAG_PRG_FAIL_A 3;
BA_ "GenSigSendType" SG_ 818 PMN332_7_0_RES_CONTROL_STATUS 3;
BA_ "GenSigSendType" SG_ 818 PMN332_7_2_REQ_RES_P_LOCK 3;
BA_ "GenSigSendType" SG_ 818 PMN332_7_5_IGB_RELAY_REQ 3;
BA_ "GenSigSendType" SG_ 818 PMN332_7_6_IGA_RELAY_REQ 3;
BA_ "GenSigSendType" SG_ 818 PMN332_7_7_REQ_STOP_RES 3;
BA_ "GenSigSendType" SG_ 818 PMN332_6_0_RES_IDLE_TIME 3;
BA_ "GenSigSendType" SG_ 818 PMN332_6_7_CUST 3;
BA_ "GenSigSendType" SG_ 818 PMN332_5_0_PUSHSTART_SW 3;
BA_ "GenSigSendType" SG_ 818 PMN332_5_1_SIG_KEY_PUSHSTART 3;
BA_ "GenSigSendType" SG_ 818 PMN332_5_2_STATE_MODE_POWER 3;
BA_ "GenSigSendType" SG_ 818 PMN332_5_4_BUZ_2SHOT_IN 3;
BA_ "GenSigSendType" SG_ 818 PMN332_5_5_BUZ_INTERMIT1_IN 3;
BA_ "GenSigSendType" SG_ 818 PMN332_5_6_BUZ_INTERMIT2_IN 3;
BA_ "GenSigSendType" SG_ 818 PMN332_5_7_BUZ_CONTINUE_IN 3;
BA_ "GenSigSendType" SG_ 818 PMN332_2_0_WARN_SSP_SIG1 3;
BA_ "GenSigSendType" SG_ 818 PMN332_2_1_WARN_SSP_SIG2 3;
BA_ "GenSigSendType" SG_ 818 PMN332_2_4_SMT_PWR_SIG 3;
BA_ "GenSigSendType" SG_ 818 PMN332_2_7_BUZ_1SHOT_IN 3;
BA_ "GenSigSendType" SG_ 1603 SMT643_2_0_DATA2 4;
BA_ "GenSigSendType" SG_ 1603 SMT643_1_4_DATA1 4;
BA_ "GenSigSendType" SG_ 1601 SMT641_5_0_RKE_BODY_INF_BYTE3 2;
BA_ "GenSigSendType" SG_ 1601 SMT641_4_0_RKE_BODY_INF_BYTE2 2;
BA_ "GenSigSendType" SG_ 1601 SMT641_3_0_RKE_BODY_INF_BYTE1 2;
BA_ "GenSigSendType" SG_ 1601 SMT641_2_0_RKE_BODY_CTL_BYTE 2;
BA_ "GenSigSendType" SG_ 1600 SMT640_7_0_RES_CONTROL_STATUS 3;
BA_ "GenSigSendType" SG_ 1600 SMT640_7_2_REQ_RES_P_LOCK 3;
BA_ "GenSigSendType" SG_ 1600 SMT640_7_4_KEY_STATUS 3;
BA_ "GenSigSendType" SG_ 1600 SMT640_7_5_KEY_SEARCH_RESULT 3;
BA_ "GenSigSendType" SG_ 1600 SMT640_7_7_REQ_STOP_RES 3;
BA_ "GenSigSendType" SG_ 1600 SMT640_6_0_RES_IDLE_TIME 3;
BA_ "GenSigSendType" SG_ 1600 SMT640_5_1_IND_SECURITY 3;
BA_ "GenSigSendType" SG_ 1600 SMT640_5_3_BUZ_WAL_WIUL_PAUSE 3;
BA_ "GenSigSendType" SG_ 1600 SMT640_5_4_BUZ_ALA_MAX 3;
BA_ "GenSigSendType" SG_ 1600 SMT640_5_5_PRG_LOCK_SW_STATE 3;
BA_ "GenSigSendType" SG_ 1600 SMT640_3_0_VERIFY_VALUE_OUT 3;
BA_ "GenSigSendType" SG_ 1600 SMT640_2_0_BUZ_NUM_OUT 1;
BA_ "GenSigSendType" SG_ 1600 SMT640_2_4_BUZ_PAT_OUT 1;
BA_ "GenSigSendType" SG_ 816 SMT330_7_0 3;
BA_ "GenSigSendType" SG_ 816 SMT330_7_1 3;
BA_ "GenSigSendType" SG_ 816 SMT330_7_3_HF_CAPA_ERR_ST 3;
BA_ "GenSigSendType" SG_ 816 SMT330_7_6_HF_RESP_ERR_ST 3;
BA_ "GenSigSendType" SG_ 816 SMT330_6_0_REQ_MESS_PUSHSTART 3;
BA_ "GenSigSendType" SG_ 816 SMT330_6_4_WARN_SSP_SIG1 3;
BA_ "GenSigSendType" SG_ 816 SMT330_5_1_WIUL_CUST 3;
BA_ "GenSigSendType" SG_ 816 SMT330_5_2_WAL_CUST 3;
BA_ "GenSigSendType" SG_ 816 SMT330_5_3_WARN_SSP_SIG2 3;
BA_ "GenSigSendType" SG_ 816 SMT330_5_5_WARN_SSP_SIG3 3;
BA_ "GenSigSendType" SG_ 816 SMT330_4_0_PUSHSTART_SW 3;
BA_ "GenSigSendType" SG_ 816 SMT330_4_1_SIG_KEY_PUSHSTART 3;
BA_ "GenSigSendType" SG_ 816 SMT330_4_2_HF_TOUCH_STATUS 3;
BA_ "GenSigSendType" SG_ 816 SMT330_4_5_HF_KICK_STATUS 3;
BA_ "GenSigSendType" SG_ 816 SMT330_3_0_BUZ_1SHOT_IN 3;
BA_ "GenSigSendType" SG_ 816 SMT330_3_1_BUZ_2SHOT_IN 3;
BA_ "GenSigSendType" SG_ 816 SMT330_3_2_BUZ_INTERMIT1_IN 3;
BA_ "GenSigSendType" SG_ 816 SMT330_3_3_BUZ_INTERMIT2_IN 3;
BA_ "GenSigSendType" SG_ 816 SMT330_3_4_BUZ_CONTINUE_IN 3;
BA_ "GenSigSendType" SG_ 816 SMT330_3_5_BUZ_TRPON_OK_IN 3;
BA_ "GenSigSendType" SG_ 816 SMT330_3_6_STATE_MODE_POWER 3;
BA_ "GenSigSendType" SG_ 1759 BIU6DF_2_1_ALARM_DATA 3;
BA_ "GenSigSendType" SG_ 1759 BIU6DF_1_1_DATA 3;
BA_ "GenSigSendType" SG_ 1620 BIU654_7_4_KEYSW 3;
BA_ "GenSigSendType" SG_ 1620 BIU654_7_5_ALARM 3;
BA_ "GenSigSendType" SG_ 1620 BIU654_7_6_RES_STOP_JPN 3;
BA_ "GenSigSendType" SG_ 1620 BIU654_6_0_CONT_DATA_FOR_RES 3;
BA_ "GenSigSendType" SG_ 1620 BIU654_2_0_CODE_IMB_FOR_RES 3;
BA_ "GenSigSendType" SG_ 1618 BIU652_7_0_IND_SECURITY_IMB 3;
BA_ "GenSigSendType" SG_ 1618 BIU652_6_0_OCCUPATION_3RDRH 3;
BA_ "GenSigSendType" SG_ 1618 BIU652_6_1_OCCUPATION_3RDCTR 3;
BA_ "GenSigSendType" SG_ 1618 BIU652_6_2_OCCUPATION_3RDLH 3;
BA_ "GenSigSendType" SG_ 1618 BIU652_6_3_OCCUPATION_RRRH 3;
BA_ "GenSigSendType" SG_ 1618 BIU652_6_4_OCCUPATION_RRCTR 3;
BA_ "GenSigSendType" SG_ 1618 BIU652_6_5_OCCUPATION_RRLH 3;
BA_ "GenSigSendType" SG_ 1618 BIU652_6_6_HORNHAZARD_RES_SIG 3;
BA_ "GenSigSendType" SG_ 1618 BIU652_6_7_OCCUPATION_DRVR 3;
BA_ "GenSigSendType" SG_ 1618 BIU652_5_0_STATUS_ROOMLAMP 3;
BA_ "GenSigSendType" SG_ 1618 BIU652_5_3_HEADLAMP_SMALL 3;
BA_ "GenSigSendType" SG_ 1618 BIU652_5_4_ALL_UNLOCK_STATE 3;
BA_ "GenSigSendType" SG_ 1618 BIU652_5_5_DRVR_UNLOCK_STATE 3;
BA_ "GenSigSendType" SG_ 1618 BIU652_5_6_ALL_LOCK_STATE 3;
BA_ "GenSigSendType" SG_ 1618 BIU652_4_0_TRIG_LOCK_UNLOCK 3;
BA_ "GenSigSendType" SG_ 1618 BIU652_3_0_DOOR_DRVR 3;
BA_ "GenSigSendType" SG_ 1618 BIU652_3_1_DOOR_PASS 3;
BA_ "GenSigSendType" SG_ 1618 BIU652_3_2_DOOR_RRRH 3;
BA_ "GenSigSendType" SG_ 1618 BIU652_3_3_DOOR_RRLH 3;
BA_ "GenSigSendType" SG_ 1618 BIU652_3_4_DOOR_RG 3;
BA_ "GenSigSendType" SG_ 1618 BIU652_3_5_DOOR_TR 3;
BA_ "GenSigSendType" SG_ 1618 BIU652_3_7_OPENSW_RG 3;
BA_ "GenSigSendType" SG_ 1618 BIU652_2_0_LOCKSTATUS_DRVR 3;
BA_ "GenSigSendType" SG_ 1618 BIU652_2_1_LOCKSTATUS_PASS 3;
BA_ "GenSigSendType" SG_ 1618 BIU652_2_2_LOCKSTATUS_RRRH 3;
BA_ "GenSigSendType" SG_ 1618 BIU652_2_3_LOCKSTATUS_RRLH 3;
BA_ "GenSigSendType" SG_ 1618 BIU652_2_4_LOCKSTATUS_RG 3;
BA_ "GenSigSendType" SG_ 1618 BIU652_2_6_UNLOCK_DOORKEYSW 3;
BA_ "GenSigSendType" SG_ 1618 BIU652_2_7_LOCK_DOORKEYSW 3;
BA_ "GenSigSendType" SG_ 1617 BIU651_7_0_PWPOS_RL 3;
BA_ "GenSigSendType" SG_ 1617 BIU651_7_2_PWPOS_RR 3;
BA_ "GenSigSendType" SG_ 1617 BIU651_7_4_PWPOS_PASS 3;
BA_ "GenSigSendType" SG_ 1617 BIU651_7_6_PWPOS_DRVR 3;
BA_ "GenSigSendType" SG_ 1617 BIU651_6_0_IND_ACTIVE_HBA 3;
BA_ "GenSigSendType" SG_ 1617 BIU651_6_2_ADB_ACTIVE 3;
BA_ "GenSigSendType" SG_ 1617 BIU651_6_3_JUDGE_ILL 3;
BA_ "GenSigSendType" SG_ 1617 BIU651_6_4_TYPE_LO_BEAM 3;
BA_ "GenSigSendType" SG_ 1617 BIU651_6_6_TYPE_HI_BEAM 3;
BA_ "GenSigSendType" SG_ 1617 BIU651_5_0_SRF_ACTIVE 3;
BA_ "GenSigSendType" SG_ 1617 BIU651_5_1_SRF_IND 3;
BA_ "GenSigSendType" SG_ 1617 BIU651_5_3_SRF_LAMP_LIGHT 3;
BA_ "GenSigSendType" SG_ 1617 BIU651_5_4_SRF_LAMP_LEFT 3;
BA_ "GenSigSendType" SG_ 1617 BIU651_5_5_MSG_STATUS_HBA 3;
BA_ "GenSigSendType" SG_ 1617 BIU651_5_7_IND_FAIL_HBA 3;
BA_ "GenSigSendType" SG_ 1617 BIU651_4_0_BUZ_PATTERN 3;
BA_ "GenSigSendType" SG_ 1617 BIU651_4_4_CSTM_OPE_ALARM 3;
BA_ "GenSigSendType" SG_ 1617 BIU651_4_6_CSTM_HBA 3;
BA_ "GenSigSendType" SG_ 1617 BIU651_3_0_HEADLAMP_PASS_SW 3;
BA_ "GenSigSendType" SG_ 1617 BIU651_3_1_HEADLAMP_AUTO_SW 3;
BA_ "GenSigSendType" SG_ 1617 BIU651_3_2_JUDGE_DOOR_LOCK 3;
BA_ "GenSigSendType" SG_ 1617 BIU651_3_3_JUDGE_DOOR_UNLOCK 3;
BA_ "GenSigSendType" SG_ 1617 BIU651_3_4_HEADLAMP_Lo_SW 3;
BA_ "GenSigSendType" SG_ 1617 BIU651_3_5_HEADLAMP_HI_SW 3;
BA_ "GenSigSendType" SG_ 1617 BIU651_3_6_WIPER_AUTO_SW 3;
BA_ "GenSigSendType" SG_ 1617 BIU651_3_7_PRG_LIN_MEMORY_ON_OFF 3;
BA_ "GenSigSendType" SG_ 1617 BIU651_2_0_CSTM_ILLUMI_SSR 3;
BA_ "GenSigSendType" SG_ 1617 BIU651_2_1_HANDLE 3;
BA_ "GenSigSendType" SG_ 1617 BIU651_2_2_CSTM_SMT 3;
BA_ "GenSigSendType" SG_ 1617 BIU651_2_3_AJARDOOR_STATUS 3;
BA_ "GenSigSendType" SG_ 1617 BIU651_2_4_ONETOUCH_LAMP_OUT 3;
BA_ "GenSigSendType" SG_ 1617 BIU651_2_5_PRG_FAIL_FLAG 3;
BA_ "GenSigSendType" SG_ 1617 BIU651_2_6_CSTM_PSMECU 3;
BA_ "GenSigSendType" SG_ 1617 BIU651_2_7_STATE_REGIST_DEL 3;
BA_ "GenSigSendType" SG_ 1617 BIU651_1_4_SRPOS 3;
BA_ "GenSigSendType" SG_ 1617 BIU651_1_7_WIPER_INT_STATUS 3;
BA_ "GenSigStartValue" SG_ 942 BIU3AE_5_0_WIPER_FT_VOLUME 2;
BA_ "Fhi_SignalComment" SG_ 811 EPB32B_6_0_VEHICLE_RUN_STOP_FLG "-

";
BA_ "Fhi_SignalComment" SG_ 811 EPB32B_5_0_FLG_AVH_OILPRES_EPB "-

";
BA_ "Fhi_SignalComment" SG_ 811 EPB32B_5_1_FLG_AVH "-

";
BA_ "Fhi_SignalComment" SG_ 811 EPB32B_5_2_AVH_INTENSIFY_PRES "-

";
BA_ "Fhi_SignalComment" SG_ 811 EPB32B_5_3_BREAK_IND "-

";
BA_ "Fhi_SignalComment" SG_ 811 EPB32B_5_5_AVH_ON_LAMP "-

";
BA_ "Fhi_SignalComment" SG_ 811 EPB32B_4_0_BUZZER "-

";
BA_ "Fhi_SignalComment" SG_ 811 EPB32B_4_2_HILL_HOLD_ON_LAMP "-

";
BA_ "Fhi_SignalComment" SG_ 811 EPB32B_4_3_CLAMP_LAMP "-

";
BA_ "Fhi_SignalComment" SG_ 811 EPB32B_4_5_WARN_LAMP "-

";
BA_ "Fhi_SignalComment" SG_ 811 EPB32B_4_7_WARN_EPB_MET_LCD "-

";
BA_ "Fhi_SignalComment" SG_ 811 EPB32B_3_0_STATUS_EPB "-

";
BA_ "Fhi_SignalComment" SG_ 811 EPB32B_3_3_DYNAMIC_PARKING "-

";
BA_ "Fhi_SignalComment" SG_ 811 EPB32B_3_4_HILL_HOLD_RUN_FLG "-

";
BA_ "Fhi_SignalComment" SG_ 811 EPB32B_3_5_INHIBIT_ISS_DELAY "-

";
BA_ "Fhi_SignalComment" SG_ 811 EPB32B_3_6_INHIBIT_ISS "-

";
BA_ "Fhi_SignalComment" SG_ 811 EPB32B_2_0_ERR_INFO "-

";
BA_ "Fhi_SignalComment" SG_ 811 EPB32B_2_2_EPB_FAIL_FLG1 "-

";
BA_ "Fhi_SignalComment" SG_ 811 EPB32B_2_3_EPB_FAIL_FLG2 "-

";
BA_ "Fhi_SignalComment" SG_ 811 EPB32B_2_4_EPB_FAIL_FLG3 "-

";
BA_ "Fhi_SignalComment" SG_ 811 EPB32B_1_5_REQ_COMM_CONT "-

";
BA_ "Fhi_SignalComment" SG_ 316 VDC13C_7_0_RCV_FAIL_ADA "EyeSight対応以外は『0固定』

";
BA_ "Fhi_SignalComment" SG_ 316 VDC13C_7_1_FAIL_PCU "EyeSight対応以外は『0固定』

";
BA_ "Fhi_SignalComment" SG_ 316 VDC13C_7_2_CONT_STATE_ES_BRAKE "EyeSight対応以外は『0固定』

";
BA_ "Fhi_SignalComment" SG_ 316 VDC13C_7_3_ASST_PRECRUSH_ACC "EyeSight対応以外は『0固定』

";
BA_ "Fhi_SignalComment" SG_ 316 VDC13C_7_4_CONT_STATE_PRECRUSH "EyeSight対応以外は『0固定』

";
BA_ "Fhi_SignalComment" SG_ 316 VDC13C_7_5_PERMIT_BRAKE_ACC "EyeSight対応以外は『0固定』

";
BA_ "Fhi_SignalComment" SG_ 316 VDC13C_7_6_DETECT_BRAKING "EyeSight対応以外は『0固定』

";
BA_ "GenSigStartValue" SG_ 316 VDC13C_6_6_VDC_OFF 1;
BA_ "Fhi_SignalComment" SG_ 316 VDC13C_5_7_ACTIVATE_TSM "BF4：「0：非制御中」固定

";
BA_ "Fhi_SignalComment" SG_ 316 VDC13C_1_7_STATUS_BRAKELAMP "EyeSight対応以外は『0固定』

";
BA_ "Fhi_SignalComment" SG_ 315 VDC13B_7_0_ACCELERATE_F_R "補正値

";
BA_ "Fhi_SignalComment" SG_ 315 VDC13B_6_0_ACCELERATE_L_R "補正値

";
BA_ "GenSigStartValue" SG_ 315 VDC13B_4_0_ENG_TRQ_DOWN 65535;
BA_ "GenSigStartValue" SG_ 313 VDC139_7_4_FAIL_PRESSURE_SSR 1;
BA_ "Fhi_SignalComment" SG_ 313 VDC139_7_5_STATUS_EPB "-

";
BA_ "GenSigStartValue" SG_ 313 VDC139_4_3_FAIL_BRAKELAMPSW 1;
BA_ "GenSigStartValue" SG_ 313 VDC139_3_5_FAIL_VDC_SSR 1;
BA_ "GenSigStartValue" SG_ 313 VDC139_3_6_FAIL_SPD_SSR_FHI 1;
BA_ "GenSigStartValue" SG_ 313 VDC139_3_7_FAIL_ABS_SYS 1;
BA_ "Fhi_SignalComment" SG_ 313 VDC139_2_0_SPD_WHEEL_AVE "GW:ID139-B3b4~B2b0→ID270-B5b4~B4b0

";
BA_ "GenSigStartValue" SG_ 313 VDC139_1_4_FAIL_HDC_SYS 1;
BA_ "Fhi_SignalComment" SG_ 313 VDC139_1_5_VEHICLE_HIGHT "XUVは「01:OBK」/北米SPORT_OBKは「10:標準」を送信

";
BA_ "Fhi_SignalComment" SG_ 312 VDC138_7_0_PRESSURE_WC_FTLH "EyeSight対応以外は『0固定』

";
BA_ "Fhi_SignalComment" SG_ 312 VDC138_6_0_PRESSURE_WC_FTRH "EyeSight対応以外は『0固定』

";
BA_ "Fhi_SignalComment" SG_ 312 VDC138_4_0_YAW_RATE "補正値

";
BA_ "Fhi_SignalComment" SG_ 312 VDC138_2_0_STEER_ANGLE "補正値

";
BA_ "GenSigStartValue" SG_ 952 CCU3B8_4_3_ACPANEL_SEAT_V_TEMP_P 3;
BA_ "GenSigStartValue" SG_ 952 CCU3B8_4_0_ACPANEL_SEAT_V_TEMP_D 3;
BA_ "GenSigStartValue" SG_ 952 CCU3B8_3_3_ACPANEL_SEAT_H_TEMP_P 3;
BA_ "GenSigStartValue" SG_ 952 CCU3B8_3_0_ACPANEL_SEAT_H_TEMP_D 3;
BA_ "GenSigStartValue" SG_ 1647 MCL66F_7_0_CUR_POS_H_MIR_LMR 2500;
BA_ "GenSigStartValue" SG_ 1647 MCL66F_5_0_CUR_POS_V_MIR_LMR 2500;
BA_ "GenSigStartValue" SG_ 1642 MCR66A_7_0_CUR_POS_H_MIR_RMR 2500;
BA_ "GenSigStartValue" SG_ 1642 MCR66A_5_0_CUR_POS_V_MIR_RMR 2500;
BA_ "GenSigSendType" SG_ 1610 SMT64A_1_0_IADKCD 2;
BA_ "GenSigSendType" SG_ 1610 SMT64A_0_0_RGMDDK1 2;
BA_ "GenSigSendType" SG_ 1604 SMT644_6_0_RSPRECK 3;
BA_ "GenSigSendType" SG_ 1604 SMT644_5_0_SPMODEID 3;
BA_ "GenSigSendType" SG_ 1604 SMT644_4_0_RSLT_OWCK 1;
BA_ "GenSigSendType" SG_ 1604 SMT644_3_0_OSSTARID 3;
BA_ "GenSigSendType" SG_ 1604 SMT644_3_4_NUM_NFCCARD 3;
BA_ "GenSigSendType" SG_ 1604 SMT644_2_0_RQISME 3;
BA_ "GenSigSendType" SG_ 1604 SMT644_2_4_RQISDEVI 3;
BA_ "GenSigSendType" SG_ 1604 SMT644_1_0_MSG_COUNTER 3;
BA_ "GenSigSendType" SG_ 1604 SMT644_0_0_CHECK_SUM 3;
BA_ "GenSigSendType" SG_ 1820 DKY71C_DIAG_DATA 2;
BA_ "GenSigSendType" SG_ 1812 CECU714_DIAG_DATA 2;
BA_ "GenSigSendType" SG_ 1612 DKY64C_5_0_DKY_ID 2;
BA_ "GenSigSendType" SG_ 1612 DKY64C_5_6_DKY_RSLT 2;
BA_ "GenSigSendType" SG_ 1612 DKY64C_4_0_RSRGDK 2;
BA_ "GenSigSendType" SG_ 1612 DKY64C_2_0_DKYSID 2;
BA_ "GenSigSendType" SG_ 1612 DKY64C_0_0_DKRGNGFC 2;
BA_ "GenSigSendType" SG_ 1608 DKY648_5_0_MACD2 1;
BA_ "GenSigSendType" SG_ 1608 DKY648_4_0_MACD1 1;
BA_ "GenSigSendType" SG_ 1608 DKY648_4_4_FVD 1;
BA_ "GenSigSendType" SG_ 1608 DKY648_3_0_TMIDD 1;
BA_ "GenSigSendType" SG_ 1608 DKY648_3_3_WCNTD 1;
BA_ "GenSigSendType" SG_ 1608 DKY648_1_1_WINFD 1;
BA_ "GenSigSendType" SG_ 1608 DKY648_0_4_KTYPED 1;
BA_ "GenSigSendType" SG_ 1607 DKY647_5_0_DKSENMC2 2;
BA_ "GenSigSendType" SG_ 1607 DKY647_4_0_DKSENMC1 2;
BA_ "GenSigSendType" SG_ 1607 DKY647_4_4_DKSENFV 2;
BA_ "GenSigSendType" SG_ 1607 DKY647_2_5_DKSEN1ME 2;
BA_ "GenSigSendType" SG_ 1607 DKY647_1_2_DKSEN1ID 2;
BA_ "GenSigSendType" SG_ 1607 DKY647_1_6_DKSEN1AR2 2;
BA_ "GenSigSendType" SG_ 1607 DKY647_0_0_DKSEN1AR1 2;
BA_ "GenSigSendType" SG_ 1607 DKY647_0_2_DKSENUNL 2;
BA_ "GenSigSendType" SG_ 1607 DKY647_0_4_DKSENLOC 2;
BA_ "GenSigSendType" SG_ 1607 DKY647_0_6_DKSENCNT 2;
BA_ "GenSigSendType" SG_ 1737 DKY6C9_0_0_DKIACD 2;
BA_ "GenSigSendType" SG_ 1575 DKY627_6_0_SDRGT 3;
BA_ "GenSigSendType" SG_ 1575 DKY627_2_0_FRNDFDEOUT 3;
BA_ "GenSigSendType" SG_ 1575 DKY627_0_5_SPNUM 3;
BA_ "GenSigSendType" SG_ 1574 DKY626_2_5_PS_OPSTD 3;
BA_ "GenSigSendType" SG_ 1573 DKY625_0_6_DK_REGST 3;
BA_ "GenSigSendType" SG_ 1571 DKY623_1_3_SPMDEDK 3;
BA_ "GenSigSendType" SG_ 1571 DKY623_0_2_DKINDCST 3;
BA_ "GenSigSendType" SG_ 1571 DKY623_0_4_BZRQ_DK 3;
BA_ "GenSigSendType" SG_ 1565 DKY61D_0_0_D_DKIA7 1;
BA_ "GenSigSendType" SG_ 1564 DKY61C_0_0_D_DKIA6 1;
BA_ "GenSigSendType" SG_ 1563 DKY61B_0_0_D_DKIA5 1;
BA_ "GenSigSendType" SG_ 1562 DKY61A_0_0_D_DKIA4 1;
BA_ "GenSigSendType" SG_ 1561 DKY619_0_0_D_DKIA3 2;
BA_ "GenSigSendType" SG_ 1560 DKY618_0_0_D_DKIA2 2;
BA_ "GenSigSendType" SG_ 1559 DKY617_0_0_D_DKIA1 2;
BA_ "GenSigSendType" SG_ 1556 DKY614_5_0_RSDKMC2 2;
BA_ "GenSigSendType" SG_ 1556 DKY614_4_0_RSDKMC1 2;
BA_ "GenSigSendType" SG_ 1556 DKY614_4_4_RSDKFV 2;
BA_ "GenSigSendType" SG_ 1556 DKY614_3_0_RSDK2ME 2;
BA_ "GenSigSendType" SG_ 1556 DKY614_3_5_RSDK2ID2 2;
BA_ "GenSigSendType" SG_ 1556 DKY614_2_0_RSDK2ID1 2;
BA_ "GenSigSendType" SG_ 1556 DKY614_2_1_RSDK2SAR 2;
BA_ "GenSigSendType" SG_ 1556 DKY614_2_5_RSDK1ME 2;
BA_ "GenSigSendType" SG_ 1556 DKY614_1_2_RSDK1ID 2;
BA_ "GenSigSendType" SG_ 1556 DKY614_1_6_RSDK1AR2 2;
BA_ "GenSigSendType" SG_ 1556 DKY614_0_0_RSDK1AR1 2;
BA_ "GenSigSendType" SG_ 1556 DKY614_0_2_RSDKNF 2;
BA_ "GenSigSendType" SG_ 1556 DKY614_0_4_RSDKCNT 2;
BA_ "GenSigSendType" SG_ 1556 DKY614_0_6_RSDKIDTS 2;
BA_ "GenSigSendType" SG_ 1555 DKY613_5_0_OSDKMC2 2;
BA_ "GenSigSendType" SG_ 1555 DKY613_4_0_OSDKMC1 2;
BA_ "GenSigSendType" SG_ 1555 DKY613_4_4_OSDKFV 2;
BA_ "GenSigSendType" SG_ 1555 DKY613_3_2_OSDKFRID 2;
BA_ "GenSigSendType" SG_ 1555 DKY613_3_6_OSDKFRNF 2;
BA_ "GenSigSendType" SG_ 1555 DKY_613_1_1_OSDKRRID 2;
BA_ "GenSigSendType" SG_ 1555 DKY613_1_5_OSKYRRNF 2;
BA_ "GenSigSendType" SG_ 1555 DKY613_1_6_OSDKPID2 2;
BA_ "GenSigSendType" SG_ 1555 DKY613_0_0_OSDKPID1 2;
BA_ "GenSigSendType" SG_ 1555 DKY613_0_2_OSDKPNF 2;
BA_ "GenSigSendType" SG_ 1555 DKY613_0_3_OSDKDID 2;
BA_ "GenSigSendType" SG_ 1555 DKY613_0_7_OSDKDNF 2;
BA_ "GenSigSendType" SG_ 1554 DKY612_5_0_RSISDKMC2 2;
BA_ "GenSigSendType" SG_ 1554 DKY612_4_0_RSISDKMC1 2;
BA_ "GenSigSendType" SG_ 1554 DKY612_4_4_RSISDKFV 2;
BA_ "GenSigSendType" SG_ 1554 DKY612_0_1_RSISDDK 2;
BA_ "GenSigSendType" SG_ 1554 DKY612_0_6_RSISDKME 2;
VAL_ 1005 AVN3ED_7_0_ACPANEL_PA_TEMP_DIAL 7 "Counterclockwise 3 count" 6 "Counterclockwise 2 count" 5 "Counterclockwise 1 count" 4 "Invalid" 3 "Clockwize 3 count" 2 "Clockwize 2 count" 1 "Clockwize 1 count" 0 "Stop" ;
VAL_ 1005 AVN3ED_7_3_ACPANEL_DR_TEMP_DIAL 7 "Counterclockwise 3 count" 6 "Counterclockwise 2 count" 5 "Counterclockwise 1 count" 4 "Invalid" 3 "Clockwize 3 count" 2 "Clockwize 2 count" 1 "Clockwize 1 count" 0 "Stop" ;
VAL_ 1723 AVN6BB_7_0_ISA_IACC_OFFSET_CSTM 20 "10" 19 "9" 18 "8" 17 "7" 16 "6" 15 "5" 14 "4" 13 "3" 12 "2" 11 "1" 10 "0" 9 "-1" 8 "-2" 7 "-3" 6 "-4" 5 "-5" 4 "-6" 3 "-7" 2 "-8" 1 "-9" 0 "-10" ;
VAL_ 1723 AVN6BB_7_5_EYE_TOLLBOOTH_DECEL 1 "ON" 0 "OFF" ;
VAL_ 1723 AVN6BB_7_6_EYE_CURVE_DECEL_CSTM 1 "ON" 0 "OFF" ;
VAL_ 1723 AVN6BB_7_7_EYE_GREEN_LIGHT_CSTM 1 "ON" 0 "OFF" ;
VAL_ 1723 AVN6BB_6_0_CCU_FAIL 1 "FAIL" 0 "NORMAL" ;
VAL_ 1723 AVN6BB_6_1_EYE_P_CR_CSTM 1 "ON" 0 "OFF" ;
VAL_ 1723 AVN6BB_6_2_EYE_ALK_B_LDW_CSTM 3 "ALK-B ON+LDW ON" 2 "ALK-B ON+LDW OFF" 1 "ALK-B OFF+LDW ON" 0 "ALK-B OFF+LDW OFF" ;
VAL_ 1723 AVN6BB_6_4_EYE_CSTM_REQ 1 "required" 0 "NOT required" ;
VAL_ 1723 AVN6BB_6_5_EYE_ELK_CSTM 1 "ON" 0 "OFF" ;
VAL_ 1723 AVN6BB_6_6_EYE_ALKB_EDGE_CSTM 1 "ON" 0 "OFF" ;
VAL_ 1723 AVN6BB_6_7_FCW_ON_OFF 1 "ON" 0 "OFF" ;
VAL_ 1723 AVN6BB_5_0_DMS_SELECT_ID 5 "ID5" 4 "ID4" 3 "ID3" 2 "ID2" 1 "ID1" 0 "DEFAULT" ;
VAL_ 1723 AVN6BB_5_4_TPMS_TH_MODE_CSTM 3 "TPMS3 SW (Towing)" 2 "TPMS2 SW (Loading)" 1 "TPMS1 SW (Normal)" 0 "No Operation" ;
VAL_ 1723 AVN6BB_5_6_DMS_SET_REQ 1 "required" 0 "NOT required" ;
VAL_ 1723 AVN6BB_5_7_DMS_RECOG_SET 1 "RECOG_ON" 0 "RECOG_OFF" ;
VAL_ 1723 AVN6BB_4_0_DMS_EDIT_REQ 15 "Operation Failure" 6 "MANUAL_SCAN" 5 "ID_CUST_DEL" 4 "ID_CUST_SET" 3 "ALL_ID_DEL" 2 "ID_DEL_SELECT" 1 "ID_REGIST" 0 "DEFAULT" ;
VAL_ 1723 AVN6BB_4_4_VEHICLE_DEMO 1 "ON" 0 "OFF (Default)" ;
VAL_ 1723 AVN6BB_4_5_SRVD_CSTM_REQ 1 "required" 0 "NOT required" ;
VAL_ 1723 AVN6BB_4_6_SEAT_RESET_REQ 1 "required" 0 "NOT required" ;
VAL_ 1723 AVN6BB_4_7_SEATAWAY_SET_CSTM 1 "required" 0 "NOT required" ;
VAL_ 1723 AVN6BB_3_0_SRVD_ON_OFF 1 "ON" 0 "OFF" ;
VAL_ 1723 AVN6BB_3_1_PRG_RESET_REQ 1 "required" 0 "NOT required" ;
VAL_ 1723 AVN6BB_3_2_PRG_MEM_CSTM 1 "required" 0 "NOT required" ;
VAL_ 1723 AVN6BB_3_3_DMS_ON_OFF 1 "ON/OFF Change" 0 "invalid" ;
VAL_ 1723 AVN6BB_3_4_MIR_RESET_REQ 1 "required" 0 "NOT required" ;
VAL_ 1723 AVN6BB_3_5_MIR_AFOLD_CSTM 1 "required" 0 "NOT required" ;
VAL_ 1723 AVN6BB_3_6_MIR_RTILT_CSTM 1 "required" 0 "NOT required" ;
VAL_ 1723 AVN6BB_3_7_EYE_TSA_CSTM 1 "TSA Enable(ISA)" 0 "TSA Disable(MSA)" ;
VAL_ 1723 AVN6BB_2_0_AVH_ON_OFF 3 "BLANK_NoInput" 2 "AVH ON_Input" 1 "AVH OFF_Input" 0 "Neutral" ;
VAL_ 1723 AVN6BB_2_2_VDC_ON_OFF 3 "BLANK_NoInput" 2 "VDC ON_Input" 1 "VDC OFF_Input" 0 "Neutral" ;
VAL_ 1723 AVN6BB_2_4_CCU_HALT_RESET 1 "Reset/Halt" 0 "Normal" ;
VAL_ 1723 AVN6BB_2_5_EYE_LDW_TIMING_CSTM 1 "LATE" 0 "EARLY" ;
VAL_ 1723 AVN6BB_2_6_FCW_CSTM 3 "OFF" 2 "FAR" 1 "NEAR" 0 "ON/NORM" ;
VAL_ 1723 AVN6BB_1_4_EYE_WARN_CSTM 1 "Steering Wheel Vibration" 0 "Buzzer" ;
VAL_ 1723 AVN6BB_1_5_EYE_FCTI_CSTM 3 "Reserve" 2 "Display + Sound" 1 "Display" 0 "OFF" ;
VAL_ 1723 AVN6BB_1_7_LDW_WARNING_ON_OFF 1 "ON" 0 "OFF" ;
VAL_ 1722 AVN6BA_7_0_GUIDE_LINE_REAR 1 "ON" 0 "OFF" ;
VAL_ 1722 AVN6BA_7_1_GUIDE_LINE_SIDE 1 "ON" 0 "OFF" ;
VAL_ 1722 AVN6BA_7_2_GUIDE_LINE_FRONT 1 "ON" 0 "OFF" ;
VAL_ 1722 AVN6BA_7_3_STEER_ANGLE_INTERLOCK 1 "ON" 0 "OFF" ;
VAL_ 1722 AVN6BA_7_4_BACK_CAMERA_DELAY 1 "ON" 0 "OFF" ;
VAL_ 1722 AVN6BA_7_5_REQ_STOP_CAMERA_OUT 1 "REQ" 0 "NON_REQ" ;
VAL_ 1722 AVN6BA_7_6_VIEW_CHANGE_SW 3 "NO_DEFINITION" 2 "LONG_PUSH" 1 "SHORT_PUSH" 0 "INVALID" ;
VAL_ 1722 AVN6BA_6_6_CLIMATE_SYNC 1 "ON/OFF Change" 0 "invalid" ;
VAL_ 1722 AVN6BA_6_7_CLIMATE_F_DEF 1 "ON/OFF Change" 0 "invalid" ;
VAL_ 1722 AVN6BA_5_6_CLIMAITE_AUTO 1 "FULL AUTO ON" 0 "invalid" ;
VAL_ 1722 AVN6BA_5_7_CLIMAITE_MAX_AC 1 "ON/OFF Change" 0 "invalid" ;
VAL_ 1722 AVN6BA_4_0_CLIMAITE_VR 4 "Voice recognition" 0 "No voice recognition" ;
VAL_ 1722 AVN6BA_4_3_CLIMATE_AC 1 "ON/OFF Change" 0 "invalid" ;
VAL_ 1722 AVN6BA_4_4_CLIMAITE_FAN 15 "No change" 14 "Reserve" 13 "Reserve" 12 "Reserve" 11 "Reserve" 10 "Reserve" 9 "Reserve" 8 "Reserve" 7 "HI" 6 "M5" 5 "M4" 4 "M3" 3 "M2" 2 "M1" 1 "LO" 0 "invalid" ;
VAL_ 1722 AVN6BA_3_0_PERSONAL_IC_SH 7 "Reserve" 6 "Reserve" 5 "Reserve" 4 "Reserve" 3 "type C" 2 "type B" 1 "type A" 0 "No information" ;
VAL_ 1722 AVN6BA_3_4_CSTM_SONNER 1 "ON" 0 "OFF" ;
VAL_ 1722 AVN6BA_3_5_CSTM_RAB 1 "ON" 0 "OFF" ;
VAL_ 1722 AVN6BA_3_6_REQ_CHG_CSTM_RAB 1 "request" 0 "no request" ;
VAL_ 1722 AVN6BA_3_7_CLIMATE_R_DEF 1 "ON/OFF Change" 0 "invalid" ;
VAL_ 1722 AVN6BA_2_0_CLIMATE_PTC 1 "ON/OFF Change" 0 "invalid" ;
VAL_ 1722 AVN6BA_2_1_CLIMATE_MODE 1 "ON/OFF Change" 0 "invalid" ;
VAL_ 1722 AVN6BA_2_2_CLIMATE_SEAT_C_L 1 "ON/OFF Change" 0 "invalid" ;
VAL_ 1722 AVN6BA_2_3_CLIMATE_SEAT_C_R 1 "ON/OFF Change" 0 "invalid" ;
VAL_ 1722 AVN6BA_2_4_CLIMATE_SEAT_H_L 1 "ON/OFF Change" 0 "invalid" ;
VAL_ 1722 AVN6BA_2_5_CLIMATE_SEAT_H_R 1 "ON/OFF Change" 0 "invalid" ;
VAL_ 1722 AVN6BA_2_6_CLIMATE_INNER_AIR 1 "ON/OFF Change" 0 "invalid" ;
VAL_ 1722 AVN6BA_2_7_CLIMATE_ON_OFF 1 "ON/OFF Change" 0 "invalid" ;
VAL_ 1722 AVN6BA_1_4_CLIMAITE_STATUS 7 "Not Found" 6 "Detected" 5 "Replay" 4 "Loading" 3 "Accepting" 2 "Ready" 1 "Standby" 0 "Start up" ;
VAL_ 1722 AVN6BA_1_7_CLIMAITE_ON_OFF 1 "ON" 0 "OFF" ;
VAL_ 1019 AVN3FB_7_0_SMT_TIM_RESET_REQ 1 "required" 0 "NOT required" ;
VAL_ 1019 AVN3FB_7_1_SMT_EG_CSTM_REQ 1 "required" 0 "NOT required" ;
VAL_ 1019 AVN3FB_7_2_EYE_YEILD_CSTM 1 "ON" 0 "OFF" ;
VAL_ 1019 AVN3FB_7_3_EYE_STOP_CSTM 1 "ON" 0 "OFF" ;
VAL_ 1019 AVN3FB_7_4_EYE_NO_ENTRY_CSTM 1 "ON" 0 "OFF" ;
VAL_ 1019 AVN3FB_7_5_MVS_CAMERA_SELECT_SW 1 "SW Push Event" 0 "No Operation(SW Release Event)" ;
VAL_ 1019 AVN3FB_7_7_ACPANEL_DR_ONLY 1 "SW Push Event" 0 "invalid" ;
VAL_ 1019 AVN3FB_6_6_ACPANEL_MODE_DOWN 1 "SW Push Event" 0 "invalid" ;
VAL_ 1019 AVN3FB_6_7_ACPANEL_MODE_UP 1 "SW Push Event" 0 "invalid" ;
VAL_ 1019 AVN3FB_5_6_ACPANEL_FAN_DOWN 1 "SW Push Event" 0 "invalid" ;
VAL_ 1019 AVN3FB_5_7_ACPANEL_FAN_UP 1 "SW Push Event" 0 "invalid" ;
VAL_ 1019 AVN3FB_4_0_ACPANEL_FAN_LEVEL 15 "No change" 14 "Reserve" 13 "Reserve" 12 "Reserve" 11 "Reserve" 10 "Reserve" 9 "Reserve" 8 "Reserve" 7 "HI" 6 "M5" 5 "M4" 4 "M3" 3 "M2" 2 "M1" 1 "LO" 0 "invalid" ;
VAL_ 1019 AVN3FB_4_4_ACPANEL_MODE_VENT 15 "Invalid" 6 "DEF" 5 "FOOT/DEF" 4 "FOOT" 3 "B/L" 2 "VENTⅡ" 1 "VENT" 0 "Invalid" ;
VAL_ 1019 AVN3FB_3_0_ACPANEL_PA_TEMP_DOWN 1 "SW Push Event" 0 "invalid" ;
VAL_ 1019 AVN3FB_3_1_ACPANEL_PA_TEMP_UP 1 "SW Push Event" 0 "invalid" ;
VAL_ 1019 AVN3FB_3_2_ACPANEL_DR_TEMP_DOWN 1 "SW Push Event" 0 "invalid" ;
VAL_ 1019 AVN3FB_3_3_ACPANEL_DR_TEMP_UP 1 "SW Push Event" 0 "invalid" ;
VAL_ 1019 AVN3FB_3_4_ACPANEL_SYNC 1 "SW Push Event" 0 "invalid" ;
VAL_ 1019 AVN3FB_3_5_ACPANEL_AC 1 "SW Push Event" 0 "invalid" ;
VAL_ 1019 AVN3FB_3_6_F_DEF_SW 1 "SW Push Event" 0 "invalid" ;
VAL_ 1019 AVN3FB_3_7_R_DEF_SW 1 "SW Push Event" 0 "invalid" ;
VAL_ 1019 AVN3FB_2_0_ACPANEL_AUTO 1 "SW Push Event" 0 "invalid" ;
VAL_ 1019 AVN3FB_2_1_ACPANEL_MAX_AC 1 "SW Push Event" 0 "invalid" ;
VAL_ 1019 AVN3FB_2_2_ACPANEL_SEAT_C_P 1 "SW Push Event" 0 "invalid" ;
VAL_ 1019 AVN3FB_2_3_ACPANEL_SEAT_C_D 1 "SW Push Event" 0 "invalid" ;
VAL_ 1019 AVN3FB_2_4_ACPANEL_SEAT_H_P 1 "SW Push Event" 0 "invalid" ;
VAL_ 1019 AVN3FB_2_5_ACPANEL_SEAT_H_D 1 "SW Push Event" 0 "invalid" ;
VAL_ 1019 AVN3FB_2_6_ACPANEL_INNER_AIR 1 "SW Push Event" 0 "invalid" ;
VAL_ 1019 AVN3FB_2_7_ACPANEL_AC_ON_OFF 1 "SW Push Event" 0 "invalid" ;
VAL_ 1019 AVN3FB_1_4_EYE_CSTM_REQ_3FB 1 "required" 0 "NOT required" ;
VAL_ 1019 AVN3FB_1_5_DDAW_WARNING_CSTM 1 "ON" 0 "OFF" ;
VAL_ 1019 AVN3FB_1_6_SIGN_SWITCH_SND 1 "ON" 0 "OFF" ;
VAL_ 1019 AVN3FB_1_7_SLWF_CSTM 1 "ON" 0 "OFF" ;
VAL_ 1765 RES6E5_6_0_REQ_DOOR_LOCK_ARM 1 "REQ" 0 "NON_REQ" ;
VAL_ 1765 RES6E5_6_1_REQ_ST_ON 1 "ON" 0 "OFF" ;
VAL_ 1765 RES6E5_6_2_REQ_POWER_ON 1 "ON" 0 "OFF" ;
VAL_ 1765 RES6E5_6_3_ON_SIGN 1 "RES_ON" 0 "NON" ;
VAL_ 1765 RES6E5_5_5_REQ_PARKLIGHT_HORN 4 "ParkLightON_HORN_OFF" 3 "ParkLight&HORN_3times" 2 "ParkLight&HORN_2times" 1 "ParkLight&HORN_1time" 0 "NON_REQ" ;
VAL_ 1765 RES6E5_1_4_WAKE_UP_FRAME 1 "WakeUP_FRAME" 0 "Normal_FRAME" ;
VAL_ 1765 RES6E5_1_5_REQ_COMM_CONT 1 "REQ" 0 "NON_REQ" ;
VAL_ 1635 AHL663_3_0_FAIL_ADB 3 "NONE" 2 "BULB_CHECK" 1 "ON" 0 "OFF" ;
VAL_ 1635 AHL663_3_2_HEADLAMP_HI_IND 1 "ON" 0 "OFF" ;
VAL_ 1635 AHL663_3_3_ADB_ACTIVE_IND 1 "ON" 0 "OFF" ;
VAL_ 1635 AHL663_3_4_CSTM_SRH_OFF 1 "ON" 0 "OFF" ;
VAL_ 1635 AHL663_2_0_FAIL_AHL 7 "3_BLINK_ALARM(Only_MS2)" 6 "2_BLINK_ALARM(Only_MS2)" 5 "6_BLINK_ALARM(Only_MS2)" 4 "BULB_CHECK" 3 "2_BLINK_ALARM" 2 "3_BLINK_ALARM" 1 "ON" 0 "OFF" ;
VAL_ 1635 AHL663_2_3_FAIL_LED_HEADLAMP 3 "NONE" 2 "BULB_CHECK" 1 "ON" 0 "OFF" ;
VAL_ 1635 AHL663_2_5_IND_AFS 7 "NONE" 6 "NONE" 5 "NONE" 4 "BULB_CHECK" 3 "2_BLINK_ALARM" 2 "3_BLINK_ALARM" 1 "ON" 0 "OFF" ;
VAL_ 985 AHL3D9_1_4_AHL_STATE 1 "FAIL" 0 "Normal" ;
VAL_ 1296 PSM510_1_4_ActiveWakeUpBit 1 "active wakeup" 0 "passive wakeup" ;
VAL_ 1639 PSC667_3_0_SEAT_SW_ANOMALOUS 1 "Abnormal" 0 "Normal" ;
VAL_ 1639 PSC667_3_1_SEAT_MOT_ANOMALOUS 1 "Abnormal" 0 "Normal" ;
VAL_ 1639 PSC667_3_2_SEAT_PLS_ANOMALOUS 1 "Abnormal" 0 "Normal" ;
VAL_ 1639 PSC667_2_0_NVM_ANOMALOUS 1 "Abnormal" 0 "Normal" ;
VAL_ 1639 PSC667_2_1_POWER_ANOMALOUS 1 "Abnormal" 0 "Normal" ;
VAL_ 1638 PSC666_3_0_PSC_APPLY_CONST 7 "DEFINE_7" 6 "DEFINE_6" 5 "DEFINE_5" 4 "DEFINE_4" 3 "DEFINE_3" 2 "DEFINE_2" 1 "DEFINE_1" 0 "NO_DEFINED" ;
VAL_ 1638 PSC666_2_0_MNL_SW_TLT_SEAT 3 "Reserved" 2 "ON_MINUS" 1 "ON_PLUS" 0 "OFF" ;
VAL_ 1638 PSC666_2_2_MNL_SW_LFT_SEAT 3 "Reserved" 2 "ON_MINUS" 1 "ON_PLUS" 0 "OFF" ;
VAL_ 1638 PSC666_2_4_MNL_SW_RCL_SEAT 3 "Reserved" 2 "ON_MINUS" 1 "ON_PLUS" 0 "OFF" ;
VAL_ 1638 PSC666_2_6_MNL_SW_SLD_SEAT 3 "Reserved" 2 "ON_MINUS" 1 "ON_PLUS" 0 "OFF" ;
VAL_ 1624 PSC658_5_2_STATE_ACT_TLT 3 "Reserved" 2 "OPERATION_MINUS" 1 "OPERATION_PLUS" 0 "NO_OPERATION" ;
VAL_ 1624 PSC658_5_4_FACTOR_ACT_TLT 3 "Reserved" 2 "OPERATION_MANUAL" 1 "OPERATION" 0 "NO_OPERATION" ;
VAL_ 1624 PSC658_2_2_STATE_ACT_LFT 3 "Reserved" 2 "OPERATION_MINUS" 1 "OPERATION_PLUS" 0 "NO_OPERATION" ;
VAL_ 1624 PSC658_2_4_FACTOR_ACT_LFT 3 "Reserved" 2 "OPERATION_MANUAL" 1 "OPERATION" 0 "NO_OPERATION" ;
VAL_ 1623 PSC657_5_2_STATE_ACT_RCL 3 "Reserved" 2 "OPERATION_MINUS" 1 "OPERATION_PLUS" 0 "NO_OPERATION" ;
VAL_ 1623 PSC657_5_4_FACTOR_ACT_RCL 3 "Reserved" 2 "OPERATION_MANUAL" 1 "OPERATION" 0 "NO_OPERATION" ;
VAL_ 1623 PSC657_2_2_STATE_ACT_SLD 3 "Reserved" 2 "OPERATION_MINUS" 1 "OPERATION_PLUS" 0 "NO_OPERATION" ;
VAL_ 1623 PSC657_2_4_FACTOR_ACT_SLD 3 "Reserved" 2 "OPERATION_MANUAL" 1 "OPERATION" 0 "NO_OPERATION" ;
VAL_ 1298 MEP512_1_4_ActiveWakeUpBit 1 "active wakeup" 0 "passive wakeup" ;
VAL_ 1297 MED511_1_4_ActiveWakeUpBit 1 "active wakeup" 0 "passive wakeup" ;
VAL_ 1645 PRG66D_4_0_BUZZER_RQ_PRG 15 "吹鳴停止要求" 13 "警報Type-3 要求" 12 "警報Type-2 要求" 11 "警報Type-1 要求" 4 "ｱﾝｻｰﾊﾞｯｸType-4要求" 3 "ｱﾝｻｰﾊﾞｯｸType-3要求" 2 "ｱﾝｻｰﾊﾞｯｸType-2要求" 1 "ｱﾝｻｰﾊﾞｯｸType-1要求" 0 "吹鳴要求なし" ;
VAL_ 1645 PRG66D_4_7_PRG_HF_ON_OFF 1 "ON" 0 "OFF" ;
VAL_ 1645 PRG66D_3_1_PRG_MEMORY_ON_OFF 1 "ON" 0 "OFF" ;
VAL_ 1645 PRG66D_3_3_PRG_LOCK_SW_RQ 1 "REQUEST" 0 "NON REQUEST" ;
VAL_ 1645 PRG66D_3_5_KICK_CSTM_TIMER 7 "7秒" 6 "6秒" 5 "5秒" 4 "4秒" 3 "3秒" 2 "2秒" 1 "1秒" 0 "0秒" ;
VAL_ 1645 PRG66D_2_2_HAZARD 3 "Type-3 要求" 2 "Type-2 要求" 1 "Type-1 要求" 0 "点滅要求無" ;
VAL_ 1294 PRG50E_1_4_ActiveWakeUpBit 1 "active wakeup" 0 "passive wakeup" ;
VAL_ 1646 PRG66E_5_5_PERMIT_PRG_OPER 7 "No_Definition" 6 "No_Definition" 5 "No_Definition" 4 "PERMIT" 3 "TEMPORARY_INHIBIT(NO_ACTION)" 2 "TEMPORARY_INHIBIT(REFUSAL)" 1 "INHIBIT(FAULT)" 0 "INHIBIT(UNINITIALIZED)" ;
VAL_ 1646 PRG66E_4_0_PERM_PRG_OPER_OPEN 1 "PERMIT" 0 "INHIBIT" ;
VAL_ 1646 PRG66E_4_1_PERM_PRG_OPER_OPEN 1 "PERMIT" 0 "INHIBIT" ;
VAL_ 1646 PRG66E_4_2_FACT_PRG_OPER 7 "ASSIST_OPERATION" 6 "OPERATION_REJECTED" 5 "FAIL-SAFE2" 4 "FAIL-SAFE" 3 "JAMPRO_CLOSING" 2 "JAMPRO_OPENING" 1 "CECU_REQUEST" 0 "STOPPED" ;
VAL_ 1646 PRG66E_4_6_CUR_RG_STATE 3 "No_Definition" 2 "OPEN" 1 "FULL_CLOSE" 0 "UNKNOWN (UNLEARNED)" ;
VAL_ 1646 PRG66E_2_4_SW_PRG_PULS_CLOSE 1 "ON" 0 "OFF" ;
VAL_ 1646 PRG66E_2_5_SW_PRG_PULS_OPEN 1 "ON" 0 "OFF" ;
VAL_ 1646 PRG66E_2_6_SW_PRG_LOCK 1 "ON" 0 "OFF" ;
VAL_ 1646 PRG66E_2_7_SW_PRG_INNER 1 "ON" 0 "OFF" ;
VAL_ 1646 PRG66E_1_4_STATUS_PRG_OPER 7 "No_Definition" 6 "No_Definition" 5 "UNKNOWN" 4 "FULL_CLOSE" 3 "CLOSING" 2 "OPENING" 1 "MID_OPEN_STOP" 0 "FULL_OPEN" ;
VAL_ 1646 PRG66E_1_7_PERMIT_MEM_POS_PRG 1 "PERMIT" 0 "INHIBIT" ;
VAL_ 818 PMN332_7_0_RES_CONTROL_STATUS 3 "Termination for Remote engine start control (Termination sequence for Remote engine start control)" 2 "Remote engine start heating operation (During Remote engine start running)" 1 "Remote engine start starting control (Before engine starts)" 0 "OFF (Remote engine start uncontrolled)" ;
VAL_ 818 PMN332_7_2_REQ_RES_P_LOCK 1 "REQ_RES_P_LOCK" 0 "NON_REQ" ;
VAL_ 818 PMN332_7_7_REQ_STOP_RES 1 "REQ_STOP_RES" 0 "NON_REQ" ;
VAL_ 818 PMN332_6_7_CUST 1 "ON" 0 "OFF" ;
VAL_ 818 PMN332_5_0_PUSHSTART_SW 1 "ON" 0 "OFF" ;
VAL_ 818 PMN332_5_1_SIG_KEY_PUSHSTART 1 "Key_DEFINED" 0 "Key_NOT_DEFINED" ;
VAL_ 818 PMN332_5_2_STATE_MODE_POWER 2 "RES_Start_MODE" 1 "Pre_Air_Cond_MODE" 0 "Normal_MODE" ;
VAL_ 818 PMN332_5_4_BUZ_2SHOT_IN 1 "REQ" 0 "NON_REQ" ;
VAL_ 818 PMN332_5_5_BUZ_INTERMIT1_IN 1 "REQ" 0 "NON_REQ" ;
VAL_ 818 PMN332_5_6_BUZ_INTERMIT2_IN 1 "REQ" 0 "NON_REQ" ;
VAL_ 818 PMN332_5_7_BUZ_CONTINUE_IN 1 "REQ" 0 "NON_REQ" ;
VAL_ 818 PMN332_2_0_WARN_SSP_SIG1 1 "SMART_FAIL_WARN" 0 "NON_REQ" ;
VAL_ 818 PMN332_2_1_WARN_SSP_SIG2 4 "TIMER_RESET_DISPLAY" 3 "30S_BEFORE_ENGINE_STOP" 2 "SMART_EMERGENCY_STOP_OPERATION" 1 "SMART_FAIL_WARN" 0 "NON_REQ" ;
VAL_ 818 PMN332_2_4_SMT_PWR_SIG 2 "IGNITION_ON_IND" 1 "ACCESSORY_IND" 0 "NON_REQ" ;
VAL_ 818 PMN332_2_7_BUZ_1SHOT_IN 1 "REQ" 0 "NON_REQ" ;
VAL_ 1303 PMN517_1_4_ActiveWakeUpBit 1 "active wakeup" 0 "passive wakeup" ;
VAL_ 1600 SMT640_7_0_RES_CONTROL_STATUS 3 "Termination for Remote engine start control" 2 "Remote engine start heating operation" 1 "Remote engine start starting control" 0 "OFF" ;
VAL_ 1600 SMT640_7_2_REQ_RES_P_LOCK 1 "REQ_RES_P_LOCK" 0 "NON_REQ" ;
VAL_ 1600 SMT640_7_4_KEY_STATUS 1 "OK" 0 "NG or Checking" ;
VAL_ 1600 SMT640_7_5_KEY_SEARCH_RESULT 3 "Undefined(unused)" 2 "presence of access key" 1 "absence of access key" 0 "uncontrolled or being confirmed" ;
VAL_ 1600 SMT640_7_7_REQ_STOP_RES 1 "REQ_STOP_RES" 0 "NON_REQ" ;
VAL_ 1600 SMT640_5_1_IND_SECURITY 3 "IMB_IND_TurnOFF_PRIORITY" 2 "IMB_IND_BLINK" 1 "IMB_IND_TurnON" 0 "IMB_IND_TurnOFF" ;
VAL_ 1600 SMT640_5_3_BUZ_WAL_WIUL_PAUSE 1 "ON" 0 "OFF" ;
VAL_ 1600 SMT640_5_4_BUZ_ALA_MAX 1 "BUZZER_MAX_ON" 0 "BUZZER_MAX_OFF" ;
VAL_ 1600 SMT640_5_5_PRG_LOCK_SW_STATE 1 "PRG_LOCK_SW_ON" 0 "PRG_LOCK_SW_OFF" ;
VAL_ 1600 SMT640_2_4_BUZ_PAT_OUT 15 "BUZZER_STOP" 14 "BUZZER_Pattern_14" 6 "BUZZER_Pattern6" 0 "BUZZER_HOLD" ;
VAL_ 816 SMT330_7_3_HF_CAPA_ERR_ST 1 "error" 0 "normal" ;
VAL_ 816 SMT330_7_6_HF_RESP_ERR_ST 1 "error" 0 "normal" ;
VAL_ 816 SMT330_6_0_REQ_MESS_PUSHSTART 8 "Power_OFF_REQ_INDI" 7 "SHIFT_P_REQ_INDI" 6 "Power_OFF_by_Battery_Protect_INDI" 4 "(Reseved)" 3 "MT_EG_Start_Support_INDI" 2 "AT_EG_Start_Support2_INDI" 1 "AT_EG_Start_Support1_INDI" 0 "NON_REQ" ;
VAL_ 816 SMT330_6_4_WARN_SSP_SIG1 14 "EV_Get_Off_Safety2_INDI" 13 "EV_Get_Off_Safety1_INDI" 12 "AT_EG_Start_Support4_INDI" 11 "(Reserved)AT_EG_Start_Support3_INDI" 10 "KEY_Battery_LOW_WARN" 9 "(AS1 series only)EG_Start_OK_INDI" 8 "(AS1 series only)POWER_ON_INDI" 7 "NO_KEY_WARN" 6 "EG_Start_OK_INDI（MT）" 5 "Emergency_OPERATE_INDI_(MT)" 4 "Emergency_OPERATE_INDI_(AT)" 3 "EG_Start_OK_INDI（AT）" 2 "Steering_Lock_NON_Release_WARN" 1 "SMART_FAIL_WARN" 0 "NON_REQ" ;
VAL_ 816 SMT330_5_2_WAL_CUST 1 "SW_FAIL" 0 "Normal" ;
VAL_ 816 SMT330_5_3_WARN_SSP_SIG2 2 "SHIFT_POS_WARN" 1 "POWER_OFF_OPERATE_REQ" 0 "NON_REQ" ;
VAL_ 816 SMT330_5_5_WARN_SSP_SIG3 4 "KEY_Leaved_WARN" 3 "(Reserved)" 2 "EG_Start_OPERATE_INDI_MT" 1 "EG_Start_OPERATE_INDI_AT" 0 "NON_REQ" ;
VAL_ 816 SMT330_4_0_PUSHSTART_SW 1 "ON" 0 "OFF" ;
VAL_ 816 SMT330_4_1_SIG_KEY_PUSHSTART 1 "Key_DEFINED" 0 "Key_NOT_DEFINED" ;
VAL_ 816 SMT330_4_2_HF_TOUCH_STATUS 7 "initialize" 6 "(rezerved)" 5 "stop" 4 "stay" 3 "release" 2 "hold" 1 "approach" 0 "absence" ;
VAL_ 816 SMT330_4_5_HF_KICK_STATUS 17 "hand sensor" 16 "(reserved)" 1 "detection" 0 "undetected" ;
VAL_ 816 SMT330_3_0_BUZ_1SHOT_IN 1 "REQ" 0 "NON_REQ" ;
VAL_ 816 SMT330_3_1_BUZ_2SHOT_IN 1 "REQ" 0 "NON_REQ" ;
VAL_ 816 SMT330_3_2_BUZ_INTERMIT1_IN 1 "REQ" 0 "NON_REQ" ;
VAL_ 816 SMT330_3_3_BUZ_INTERMIT2_IN 1 "REQ" 0 "NON_REQ" ;
VAL_ 816 SMT330_3_4_BUZ_CONTINUE_IN 1 "REQ" 0 "NON_REQ" ;
VAL_ 816 SMT330_3_5_BUZ_TRPON_OK_IN 1 "REQ" 0 "NON_REQ" ;
VAL_ 816 SMT330_3_6_STATE_MODE_POWER 2 "RES_Start_MODE" 1 "Pre_Air_Cond_MODE" 0 "Normal_MODE" ;
VAL_ 816 SMT330_1_4_WAKE_UP_FRAME 1 "WakeUP_FRAME" 0 "Normal_FRAME" ;
VAL_ 816 SMT330_1_5_REQ_COMM_CONT 1 "REQ" 0 "NON_REQ" ;
VAL_ 1289 SMT509_1_4_ActiveWakeUpBit 1 "active wakeup" 0 "passive wakeup" ;
VAL_ 1759 BIU6DF_2_1_ALARM_DATA 1 "REQUEST" 0 "NO_REQUEST" ;
VAL_ 1759 BIU6DF_1_1_DATA 1 "REQUEST" 0 "NO_REQUEST" ;
VAL_ 1622 BIU656_6_0_KICK_OPEN_REQ_PRG 1 "ACTIVE" 0 "NON_ACTIVE" ;
VAL_ 1622 BIU656_6_1_KICK_CLOSE_REQ_PRG 1 "ACTIVE" 0 "NON_ACTIVE" ;
VAL_ 1622 BIU656_6_6_CARGO_LAMP_OUT 1 "Turn_ON" 0 "Turn_OFF" ;
VAL_ 1622 BIU656_6_7_PERMITT_KEY_RG_UNL 1 "PERMIT" 0 "INHIBIT" ;
VAL_ 1622 BIU656_5_0_PRG_DRVR_OPENERSW 1 "ON" 0 "OFF" ;
VAL_ 1622 BIU656_5_1_HF_PRG_OFF_SW 1 "ON" 0 "OFF" ;
VAL_ 1622 BIU656_5_2_PERMIT_OPEN_RG 1 "PERMIT" 0 "INHIBIT" ;
VAL_ 1622 BIU656_5_3_BUZ_ON_OFF 1 "ON" 0 "OFF" ;
VAL_ 1622 BIU656_5_4_PRG_DRVR_SW_PERMIT 1 "PERMIT" 0 "INHIBIT" ;
VAL_ 1622 BIU656_5_5_CSTM_HF_PRG_LOCK 1 "ACTIVE" 0 "NON_ACTIVE" ;
VAL_ 1622 BIU656_5_6_CSTM_KICK_SENSOR 1 "ACTIVE" 0 "NON_ACTIVE" ;
VAL_ 1622 BIU656_5_7_KICK_REQ_PRG 1 "ACTIVE" 0 "NON_ACTIVE" ;
VAL_ 1622 BIU656_4_0_NOT_SMT_KEY_RG_SW 3 "No_definition" 2 "Long_Key_Press" 1 "Short_Key_Press" 0 "OFF" ;
VAL_ 1622 BIU656_4_2_SMT_KEY_RG_SW 3 "No_definition" 2 "Long_Key_Press" 1 "Short_Key_Press" 0 "OFF" ;
VAL_ 1622 BIU656_4_4_OPEN_RG_OPENER_SW 3 "No_definition" 2 "Long_Key_Press" 1 "Short_Key_Press" 0 "OFF" ;
VAL_ 1622 BIU656_3_4_CHECKED_KEYNO 7 "SMT_KEY_7" 6 "SMT_KEY_6" 5 "SMT_KEY_5" 4 "SMT_KEY_4" 3 "SMT_KEY_3" 2 "SMT_KEY_2" 1 "SMT_KEY_1" 0 "Unregistered" ;
VAL_ 1622 BIU656_3_7_LOCKSTATUS_DRVR 1 "UNLOCK" 0 "LOCK" ;
VAL_ 1621 BIU655_4_0_BUZZER_PATTERN 178 "BUZ_pattern2_by_autolock" 177 "BUZ_pattern1_by_autolock" 165 "BUZ_pattern5_by_answerback" 164 "BUZ_pattern4_by_answerback" 163 "BUZ_pattern3_by_answerback" 162 "BUZ_pattern2_by_answerback" 161 "BUZ_pattern1_by_answerback" 240 "BUZ_stop_by_keyless" 145 "BUZ_pattern4_by_keyless" 129 "BUZ_pattern3_by_keyless" 225 "BUZ_pattern2_by_keyless" 97 "BUZ_pattern1_by_keyless" 0 "BUZ_hold" ;
VAL_ 1621 BIU655_3_0_BUZZER_VOL_REQ 7 "ON_duty_7" 6 "ON_duty_6" 5 "ON_duty_5" 4 "ON_duty_4" 3 "ON_duty_3" 2 "ON_duty_2" 1 "ON_duty_1" 0 "NONE" ;
VAL_ 1621 BIU655_3_3_RDEF_RELAY_REQ 1 "ON_REQ" 0 "OFF_REQ" ;
VAL_ 1621 BIU655_3_4_WIPER_DEICER_REQ 1 "ON_REQ" 0 "OFF_REQ" ;
VAL_ 1621 BIU655_3_5_FT_WIPER_REQ 3 "NON" 2 "Hi_REQ" 1 "Lo_REQ" 0 "OFF" ;
VAL_ 1621 BIU655_2_0_RR_WIPER_REQ 1 "ON_REQ" 0 "OFF_REQ" ;
VAL_ 1621 BIU655_2_1_WASHER_REQ 3 "NON" 2 "Rr_REQ" 1 "Fr_REQ" 0 "OFF" ;
VAL_ 1621 BIU655_2_3_HL_WASHER_REQ 1 "ON_REQ" 0 "OFF_REQ" ;
VAL_ 1621 BIU655_2_4_FT_FOG_RELAY_REQ 1 "ON_REQ" 0 "OFF_REQ" ;
VAL_ 1621 BIU655_2_5_HEADLAMP_HI_REQ 3 "NON" 2 "ON_REQ" 1 "Dimmer_REQ" 0 "OFF" ;
VAL_ 1621 BIU655_2_7_HEADLAMP_LO_REQ 1 "ON_REQ" 0 "OFF_REQ" ;
VAL_ 1620 BIU654_7_4_KEYSW 1 "ON" 0 "OFF" ;
VAL_ 1620 BIU654_7_5_ALARM 1 "FAIL" 0 "NORMAL" ;
VAL_ 1620 BIU654_7_6_RES_STOP_JPN 1 "REQ" 0 "NON_REQ" ;
VAL_ 1618 BIU652_7_0_IND_SECURITY_IMB 6 "WARNING by the supersonic wave sensor" 5 "WARNING by the impact sensor" 4 "ALARM by the supersonic wave sensor" 3 "ALARM by the impact sensor" 7 "ALARM by open the hood" 2 "ALARM by open the trunk" 1 "ALARM by open the door" 240 "Four flashing with the immobilize" 224 "Three flashing by the immobilizer" 208 "Two flashing by the immobilizer" 192 "One flashing by the immobilizer" 144 "Flashing by the immobilizer" 128 "Lighting by the immobilizer" 112 "Lighting by the panic mode" 96 "Wait flashing by ALARM" 80 "Flashing by ALARM" 64 "Lighting by ALARM" 0 "OFF" ;
VAL_ 1618 BIU652_6_0_OCCUPATION_3RDRH 1 "ON" 0 "OFF" ;
VAL_ 1618 BIU652_6_1_OCCUPATION_3RDCTR 1 "ON" 0 "OFF" ;
VAL_ 1618 BIU652_6_2_OCCUPATION_3RDLH 1 "ON" 0 "OFF" ;
VAL_ 1618 BIU652_6_3_OCCUPATION_RRRH 1 "ON" 0 "OFF" ;
VAL_ 1618 BIU652_6_4_OCCUPATION_RRCTR 1 "ON" 0 "OFF" ;
VAL_ 1618 BIU652_6_5_OCCUPATION_RRLH 1 "ON" 0 "OFF" ;
VAL_ 1618 BIU652_6_6_HORNHAZARD_RES_SIG 1 "ON" 0 "OFF" ;
VAL_ 1618 BIU652_6_7_OCCUPATION_DRVR 1 "ON" 0 "OFF" ;
VAL_ 1618 BIU652_5_0_STATUS_ROOMLAMP 7 "TURN_ON_α_S4" 6 "TURN_ON_α_S3A" 5 "TURN_ON_α_S3" 4 "TURN_ON_Pattern2_S2A" 3 "TURN_ON_Pattern1_S2" 2 "TURN_OFF_Pattern2_S1A" 1 "TURN_OFF_Pattern1_S1" 0 "TURN_OFF_S0" ;
VAL_ 1618 BIU652_5_3_HEADLAMP_SMALL 1 "Turn_ON" 0 "Turn_OFF" ;
VAL_ 1618 BIU652_5_4_ALL_UNLOCK_STATE 1 "ON" 0 "OFF" ;
VAL_ 1618 BIU652_5_5_DRVR_UNLOCK_STATE 1 "ON" 0 "OFF" ;
VAL_ 1618 BIU652_5_6_ALL_LOCK_STATE 1 "ON" 0 "OFF" ;
VAL_ 1618 BIU652_3_0_DOOR_DRVR 1 "OPEN" 0 "CLOSE" ;
VAL_ 1618 BIU652_3_1_DOOR_PASS 1 "OPEN" 0 "CLOSE" ;
VAL_ 1618 BIU652_3_2_DOOR_RRRH 1 "OPEN" 0 "CLOSE" ;
VAL_ 1618 BIU652_3_3_DOOR_RRLH 1 "OPEN" 0 "CLOSE" ;
VAL_ 1618 BIU652_3_4_DOOR_RG 1 "OPEN" 0 "CLOSE" ;
VAL_ 1618 BIU652_3_5_DOOR_TR 1 "OPEN" 0 "CLOSE" ;
VAL_ 1618 BIU652_3_7_OPENSW_RG 1 "ON" 0 "OFF" ;
VAL_ 1618 BIU652_2_0_LOCKSTATUS_DRVR 1 "UNLOCK" 0 "LOCK" ;
VAL_ 1618 BIU652_2_1_LOCKSTATUS_PASS 1 "UNLOCK" 0 "LOCK" ;
VAL_ 1618 BIU652_2_2_LOCKSTATUS_RRRH 1 "UNLOCK" 0 "LOCK" ;
VAL_ 1618 BIU652_2_3_LOCKSTATUS_RRLH 1 "UNLOCK" 0 "LOCK" ;
VAL_ 1618 BIU652_2_4_LOCKSTATUS_RG 1 "UNLOCK OR PERMIT_UNLOCK" 0 "LOCK OR PROHIBIT_UNLOOK" ;
VAL_ 1618 BIU652_2_6_UNLOCK_DOORKEYSW 1 "ON" 0 "OFF" ;
VAL_ 1618 BIU652_2_7_LOCK_DOORKEYSW 1 "ON" 0 "OFF" ;
VAL_ 1617 BIU651_7_0_PWPOS_RL 3 "other" 2 "ALL CLOSE" 1 "ALL OPEN" 0 "INDEFINITE" ;
VAL_ 1617 BIU651_7_2_PWPOS_RR 3 "other" 2 "ALL CLOSE" 1 "ALL OPEN" 0 "INDEFINITE" ;
VAL_ 1617 BIU651_7_4_PWPOS_PASS 3 "other" 2 "ALL CLOSE" 1 "ALL OPEN" 0 "INDEFINITE" ;
VAL_ 1617 BIU651_7_6_PWPOS_DRVR 3 "other" 2 "ALL CLOSE" 1 "ALL OPEN" 0 "INDEFINITE" ;
VAL_ 1617 BIU651_6_0_IND_ACTIVE_HBA 3 "NONE" 2 "BLINK" 1 "Turn_ON" 0 "Turn_OFF" ;
VAL_ 1617 BIU651_6_2_ADB_ACTIVE 1 "ACTIVE" 0 "NON_ACTIVE" ;
VAL_ 1617 BIU651_6_3_JUDGE_ILL 1 "ACTIVE" 0 "NON_ACTIVE" ;
VAL_ 1617 BIU651_6_4_TYPE_LO_BEAM 3 "NONE" 2 "LED" 1 "HID" 0 "HALOGEN" ;
VAL_ 1617 BIU651_6_6_TYPE_HI_BEAM 3 "NONE" 2 "LED" 1 "HID" 0 "HALOGEN" ;
VAL_ 1617 BIU651_5_0_SRF_ACTIVE 1 "ACTIVE" 0 "NON_ACTIVE" ;
VAL_ 1617 BIU651_5_1_SRF_IND 3 "NONE" 2 "BLINK" 1 "Turn_ON" 0 "Turn_OFF" ;
VAL_ 1617 BIU651_5_3_SRF_LAMP_LIGHT 1 "Turn_ON" 0 "Turn_OFF" ;
VAL_ 1617 BIU651_5_4_SRF_LAMP_LEFT 1 "Turn_ON" 0 "Turn_OFF" ;
VAL_ 1617 BIU651_5_5_MSG_STATUS_HBA 3 "NONE" 2 "FAIL" 1 "HALT" 0 "OFF" ;
VAL_ 1617 BIU651_5_7_IND_FAIL_HBA 1 "Turn_ON" 0 "Turn_OFF" ;
VAL_ 1617 BIU651_4_0_BUZ_PATTERN 8 "NON" 7 "Customize_2" 6 "Customize_1" 5 "NON" 4 "NON" 3 "Light_Warning" 2 "Key_Warning" 1 "Reverse_BUZZ" 0 "BUZZ_STOP" ;
VAL_ 1617 BIU651_4_4_CSTM_OPE_ALARM 3 "NON" 2 "OFF" 1 "ON" 0 "BLINK" ;
VAL_ 1617 BIU651_4_6_CSTM_HBA 3 "BLANK" 2 "MIRROR_HBA" 1 "EYESIGHT_HBA" 0 "NON_ACTIVE" ;
VAL_ 1617 BIU651_3_0_HEADLAMP_PASS_SW 1 "ON" 0 "OFF" ;
VAL_ 1617 BIU651_3_1_HEADLAMP_AUTO_SW 1 "ON" 0 "OFF" ;
VAL_ 1617 BIU651_3_2_JUDGE_DOOR_LOCK 1 "REQ" 0 "NON_REQ" ;
VAL_ 1617 BIU651_3_3_JUDGE_DOOR_UNLOCK 1 "CONNECT" 0 "NON_CONNECT" ;
VAL_ 1617 BIU651_3_4_HEADLAMP_Lo_SW 1 "ON" 0 "OFF" ;
VAL_ 1617 BIU651_3_5_HEADLAMP_HI_SW 1 "ON" 0 "OFF" ;
VAL_ 1617 BIU651_3_6_WIPER_AUTO_SW 1 "ON" 0 "OFF" ;
VAL_ 1617 BIU651_3_7_PRG_LIN_MEMORY_ON_OFF 1 "ON" 0 "OFF" ;
VAL_ 1617 BIU651_2_0_CSTM_ILLUMI_SSR 1 "ACTIVE" 0 "NON_ACTIVE" ;
VAL_ 1617 BIU651_2_1_HANDLE 1 "RHD" 0 "LHD" ;
VAL_ 1617 BIU651_2_2_CSTM_SMT 1 "SMART" 0 "NOT SMART" ;
VAL_ 1617 BIU651_2_3_AJARDOOR_STATUS 1 "AJAR_DOOR" 0 "NOT_AJAR_DOOR" ;
VAL_ 1617 BIU651_2_4_ONETOUCH_LAMP_OUT 1 "ON" 0 "OFF" ;
VAL_ 1617 BIU651_2_5_PRG_FAIL_FLAG 1 "ON" 0 "OFF" ;
VAL_ 1617 BIU651_2_6_CSTM_PSMECU 1 "ACTIVE" 0 "NON_ACTIVE" ;
VAL_ 1617 BIU651_2_7_STATE_REGIST_DEL 1 "FINISIED" 0 "NOT_FINISIED" ;
VAL_ 1617 BIU651_1_4_SRPOS 7 "未使用" 6 "未使用" 5 "チルト区間で開" 4 "スライド区間で開" 3 "全閉" 2 "チルト全開" 1 "スライド全開" 0 "不定" ;
VAL_ 1617 BIU651_1_7_WIPER_INT_STATUS 1 "INT_ON" 0 "INT_OFF" ;
VAL_ 995 BIU3E3_7_2_FAIL_HUMID 1 "FAIL" 0 "NORMAL" ;
VAL_ 995 BIU3E3_5_2_FAIL_HUMID_ATM_TMP 1 "FAIL" 0 "NORMAL" ;
VAL_ 995 BIU3E3_3_2_FAIL_HUMID_GLA_TMP 1 "FAIL" 0 "NORMAL" ;
VAL_ 995 BIU3E3_3_6_STATUS_HUMID 3 "Normal" 2 "Diagnosis" 1 "Delivery_Inspection" 0 "Initialization" ;
VAL_ 995 BIU3E3_1_4_CSTM_HUMID 1 "ACTIVE" 0 "NON_ACTIVE" ;
VAL_ 995 BIU3E3_1_5_COMM_HUMID 3 "No_difinition" 2 "FAIL" 1 "NORMAL" 0 "UNDECIDED" ;
VAL_ 995 BIU3E3_1_7_RX_FAIL_HUMID 1 "FAIL" 0 "NORMAL" ;
VAL_ 994 BIU3E2_3_6_FAIL_SOL_RAD_L 1 "FAIL" 0 "NORMAL" ;
VAL_ 994 BIU3E2_3_7_FAIL_SOL_RAD_R 1 "FAIL" 0 "NORMAL" ;
VAL_ 994 BIU3E2_2_6_STATUS_SOL_RAD 3 "Normal" 2 "Diagnosis" 1 "Delivery_Inspection" 0 "Initialization" ;
VAL_ 994 BIU3E2_1_4_CSTM_SOL_RAD 1 "ACTIVE" 0 "NON_ACTIVE" ;
VAL_ 994 BIU3E2_1_5_COMM_SOL_RAD 3 "No_difinition" 2 "FAIL" 1 "NORMAL" 0 "UNDECIDED" ;
VAL_ 994 BIU3E2_1_7_RX_FAIL_SOL_RAD 1 "FAIL" 0 "NORMAL" ;
VAL_ 942 BIU3AE_5_0_WIPER_FT_VOLUME 5 "NON" 4 "Vol.5" 3 "Vol.4" 2 "Vol.3" 1 "Vol.2" 0 "Vol.1" ;
VAL_ 942 BIU3AE_4_4_FT_WIPER_FAIL 1 "FAIL" 0 "NORMAL" ;
VAL_ 942 BIU3AE_4_5_WIPER_FT 3 "AUTO" 2 "HIGH" 1 "LOW(MIST)" 0 "OFF" ;
VAL_ 942 BIU3AE_3_0_WINKER_LEVER_STATUS 5 "NON" 4 "Left_ON_Hold" 3 "Right_ON_Hold" 2 "Left_ON" 1 "Right_ON" 0 "OFF" ;
VAL_ 942 BIU3AE_3_4_WINKER_FACTOR 15 "NON" 14 "NON" 13 "Turn_Right(ActiveLaneChange)" 12 "Turn_Left(ActiveLaneChange)" 11 "Turn_Right(MinimumRiskManeuver)" 10 "Turn_Left(MinimumRiskManeuver)" 9 "OFF(MinimumRiskManeuver)" 8 "Hazard(Other)" 7 "Hazard(MinimumRiskManeuver)" 6 "Hazard(Emergency Brake)" 5 "Hazard(Hazard SW)" 4 "Turn_Right(deep push)" 3 "Turn_Right(shallow push)" 2 "Turn_Left(deep push)" 1 "Turn_Left(shallow push)" 0 "OFF" ;
VAL_ 942 BIU3AE_2_0_TURN_LAMP_FAIL_LEFT 1 "FAIL" 0 "NORMAL" ;
VAL_ 942 BIU3AE_2_1_TURN_LAMP_FAIL_RIGHT 1 "FAIL" 0 "NORMAL" ;
VAL_ 942 BIU3AE_2_3_HAZARD_SW 1 "ON" 0 "OFF" ;
VAL_ 940 BIU3AC_7_0_HEADLAMP_SMALL 1 "Turn_ON" 0 "Turn_OFF" ;
VAL_ 940 BIU3AC_7_1_HEADLAMP_LO_REQ 1 "Turn_ON" 0 "Turn_OFF" ;
VAL_ 940 BIU3AC_7_2_HEADLAMP_HI_REQ 1 "Turn_ON" 0 "Turn_OFF" ;
VAL_ 940 BIU3AC_7_3_FT_FOG_RELAY_REQ 1 "Turn_ON" 0 "Turn_OFF" ;
VAL_ 940 BIU3AC_7_4_FOGLAMP_RR 1 "Turn_ON" 0 "Turn_OFF" ;
VAL_ 940 BIU3AC_7_5_DRL 1 "Turn_ON" 0 "Turn_OFF" ;
VAL_ 940 BIU3AC_7_6_WIPER_FRONT 1 "ON" 0 "OFF" ;
VAL_ 940 BIU3AC_7_7_RDEF_RELAY_REQ 1 "ON" 0 "OFF" ;
VAL_ 940 BIU3AC_6_0_RDEFOGSW 1 "ON" 0 "OFF" ;
VAL_ 940 BIU3AC_6_1_CSTM_PRG 1 "PRG" 0 "NOT_PRG" ;
VAL_ 940 BIU3AC_6_2_FAIL_SHIFTLOCKSOL 1 "FAIL" 0 "NORMAL" ;
VAL_ 940 BIU3AC_6_3_REQ_CANCEL_ISS 1 "CANCEL" 0 "NON_CANCEL" ;
VAL_ 940 BIU3AC_6_4_REVERSE_MT 1 "REVERSE_ON" 0 "OFF" ;
VAL_ 940 BIU3AC_6_5_HANDBRAKE 1 "ON" 0 "OFF" ;
VAL_ 940 BIU3AC_6_6_BRAKELAMPSW 1 "ON" 0 "OFF" ;
VAL_ 940 BIU3AC_6_7_TOWING_SW 1 "ON" 0 "OFF" ;
VAL_ 940 BIU3AC_5_0_LANE_OFF_SW 3 "NONE" 2 "BREAKING_OF_WIRE" 1 "P-CR-OFF-SW_ON" 0 "OFF" ;
VAL_ 940 BIU3AC_5_2_PCR_OFF_SW 3 "NONE" 2 "BREAKING_OF_WIRE" 1 "P-CR-OFF-SW_ON" 0 "OFF" ;
VAL_ 940 BIU3AC_5_4_DIMMER_CANCEL 1 "ACTIVE" 0 "NON_ACTIVE" ;
VAL_ 940 BIU3AC_5_5_KEYSW 1 "ON" 0 "OFF" ;
VAL_ 940 BIU3AC_5_6_IND_ND_SHIFTLOCK 1 "表示" 0 "非表示" ;
VAL_ 940 BIU3AC_4_0_DOOR_DRVR 1 "OPEN" 0 "CLOSE" ;
VAL_ 940 BIU3AC_4_1_DOOR_PASS 1 "OPEN" 0 "CLOSE" ;
VAL_ 940 BIU3AC_4_2_DOOR_RRRH 1 "OPEN" 0 "CLOSE" ;
VAL_ 940 BIU3AC_4_3_DOOR_RRLH 1 "OPEN" 0 "CLOSE" ;
VAL_ 940 BIU3AC_4_4_DOOR_RG 1 "OPEN" 0 "CLOSE" ;
VAL_ 940 BIU3AC_4_5_DOOR_TR 1 "OPEN" 0 "CLOSE" ;
VAL_ 940 BIU3AC_4_6_HOOD_CLOSE 1 "ON" 0 "OFF" ;
VAL_ 940 BIU3AC_4_7_HOOD_OPEN 1 "ON" 0 "OFF" ;
VAL_ 940 BIU3AC_3_0_GW_STSW_RES 1 "REQ_RES_EGStart" 0 "NON_REQ_RES_EGStart" ;
VAL_ 940 BIU3AC_3_1_GW_POWER_RES 2 "RES_Start_MODE" 1 "Pre_Air_Cond_MODE" 0 "Normal_MODE" ;
VAL_ 940 BIU3AC_3_3_ST1 1 "ST" 0 "NORMAL" ;
VAL_ 940 BIU3AC_3_4_ST2 1 "ST" 0 "NORMAL" ;
VAL_ 940 BIU3AC_3_5_ACC 1 "ON" 0 "OFF" ;
VAL_ 940 BIU3AC_3_6_IGA 1 "ON" 0 "OFF" ;
VAL_ 940 BIU3AC_3_7_BAT_BACKUP 1 "ON" 0 "OFF" ;
VAL_ 940 BIU3AC_2_0_CSTM_AC 1 "ACTIVE" 0 "NON_ACTIVE" ;
VAL_ 940 BIU3AC_2_1_IMB_SMT 3 "Push&SMT" 2 "IMB_NO" 1 "IMB_YES" 0 "NON" ;
VAL_ 940 BIU3AC_2_3_CSTM_WGN_SDN 1 "WGN" 0 "SDN" ;
VAL_ 940 BIU3AC_2_4_VAL_SEAT_BACK_CTSM 1 "SEAT_BACK_ON" 0 "SEAT_BACK_OFF" ;
VAL_ 940 BIU3AC_2_5_VAL_MIR_AFOLD_CTSM 1 "MIR_AFOLD_ON" 0 "MIR_AFOLD_OFF" ;
VAL_ 940 BIU3AC_2_6_VAL_MIR_RTILT_CTSM 1 "MIR_RTILT_ON" 0 "MIR_RTILT_OFF" ;
VAL_ 940 BIU3AC_2_7_WIPER_REAR 1 "ON" 0 "OFF" ;
VAL_ 940 BIU3AC_1_4_PADDLESHIFT_DOWN_SW 1 "ON" 0 "OFF" ;
VAL_ 940 BIU3AC_1_5_PADDLESHIFT_UP_SW 1 "ON" 0 "OFF" ;
VAL_ 940 BIU3AC_1_6_MANUALMODE_SW 1 "ON" 0 "OFF" ;
VAL_ 1286 BIU506_1_4_ActiveWakeUpBit 1 "active wakeup" 0 "passive wakeup" ;
VAL_ 1616 BIU650_7_3_DOOR_LINK_SW_STS 1 "ON" 0 "OFF" ;
VAL_ 1616 BIU650_6_3_RR_WIPER_STATUS 3 "Undefined" 2 "Hi" 1 "Lo" 0 "OFF" ;
VAL_ 1616 BIU650_6_5_WIPER_SENSITIVITY_CTM 3 "4" 2 "3" 1 "2" 0 "1" ;
VAL_ 1616 BIU650_5_2_FMH_DOOR_LOCK 3 "Undefined" 2 "Unlock" 1 "Lock" 0 "No request" ;
VAL_ 1616 BIU650_5_4_LMH_DOOR_LOCK 3 "Undefined" 2 "Unlock" 1 "Lock" 0 "No request" ;
VAL_ 1616 BIU650_4_0_REQ_OPE_AUTOLIGHT 3 "Undefined" 2 "Lo" 1 "Small" 0 "OFF" ;
VAL_ 1616 BIU650_4_2_STATE_SHINSSR 3 "Normal Mode" 2 "Diagnostic Mode" 1 "Shipping Inspection Mode" 0 "Initialization Mode" ;
VAL_ 1616 BIU650_4_4_STATE_RLS_FAIL 3 "Undefined" 2 "Recovering" 1 "Abnormal" 0 "Normal" ;
VAL_ 1616 BIU650_3_0_REQ_FWASHER_ITLOCK 1 "ON" 0 "OFF" ;
VAL_ 1616 BIU650_3_1_FWIPER_RTN 1 "ON" 0 "OFF" ;
VAL_ 1616 BIU650_3_2_TURN_LAMP_STATE_LEFT 1 "Blink" 0 "OFF" ;
VAL_ 1616 BIU650_3_3_TURN_LAMP_STATE_RIGHT 1 "Blink" 0 "OFF" ;
VAL_ 1616 BIU650_2_0_HEADLAMP_SMALL_SW 1 "ON" 0 "OFF" ;
VAL_ 1616 BIU650_2_1_HEADLAMP_LO_SW 1 "ON" 0 "OFF" ;
VAL_ 1616 BIU650_2_2_HEADLAMP_OFF_SW 1 "ON" 0 "OFF" ;
VAL_ 1616 BIU650_2_3_HEADLAMP_Hi_SW 1 "ON" 0 "OFF" ;
VAL_ 1616 BIU650_2_4_HEAD_LAMP_PASS_SW 1 "ON" 0 "OFF" ;
VAL_ 1616 BIU650_2_5_FFOG_SW 1 "ON" 0 "OFF" ;
VAL_ 1616 BIU650_2_6_RFOG_SW 1 "ON" 0 "OFF" ;
VAL_ 859 DAM35B_4_0_EYE_CONTROL_FLAG 3 "undefine" 2 "undefine" 1 "Operation" 0 "No Operation" ;
VAL_ 859 DAM35B_3_0_WARNING_LAMP 3 "undefine" 2 "undefine" 1 "ON(fail)" 0 "OFF(normal)" ;
VAL_ 859 DAM35B_3_2_DAMPER_MODE 7 "undefine" 6 "undefine" 5 "undefine" 4 "undefine" 3 "Sport" 2 "Normal" 1 "Comfort" 0 "Default" ;
VAL_ 859 DAM35B_3_5_FAIL_FLAG_FOR_CCU 1 "FAIL" 0 "NORMAL" ;
VAL_ 859 DAM35B_3_6_FAIL_FLAG_DAMPER 3 "FAIL_STEP3" 2 "FAIL_STEP2" 1 "FAIL_STEP1" 0 "NORMAL" ;
VAL_ 811 EPB32B_6_0_VEHICLE_RUN_STOP_FLG 3 "reserve" 2 "ERROR" 1 "DRIVING" 0 "STOPPING" ;
VAL_ 811 EPB32B_6_2_REQ_HILL_P_CAUTION 1 "Turn_ON" 0 "Turn_OFF" ;
VAL_ 811 EPB32B_5_0_FLG_AVH_OILPRES_EPB 0 "NOT_OPERATE" 1 "OPERATE" ;
VAL_ 811 EPB32B_5_1_FLG_AVH 1 "AVH_OPERATE" 0 "AVH_NOT_OPERATE" ;
VAL_ 811 EPB32B_5_2_AVH_INTENSIFY_PRES 0 "OTHER" 1 "AVH_INTENSIFY_PRESSURE_DURING_ISS" ;
VAL_ 811 EPB32B_5_3_BREAK_IND 3 "UNDEFINED(TURN_OFF/DISPLAY OFF)" 2 "BLINK(Segment LC) or DISPLAY ON(Color LC)" 1 "TURN_ON(Segment LC) or DISPLAY ON(Color LC)" 0 "TURN_OFF(Segment LC) or DISPLAY OFF(Color LC)" ;
VAL_ 811 EPB32B_5_5_AVH_ON_LAMP 1 "ON" 0 "OFF" ;
VAL_ 811 EPB32B_5_6_AVH_FUNC_ON_LUMP 1 "ON" 0 "OFF" ;
VAL_ 811 EPB32B_5_7_AVH_ACTIVE 1 "WITH_AVH" 0 "WIITHOUT_AVH" ;
VAL_ 811 EPB32B_4_0_BUZZER 3 "CANCEL_Pi-X1" 2 "SHIFT_DISABLE_PiX2" 1 "DRIVER_BRAKE_CUE_Pi-" 0 "NO_BUZZER" ;
VAL_ 811 EPB32B_4_2_HILL_HOLD_ON_LAMP 1 "ON" 0 "OFF" ;
VAL_ 811 EPB32B_4_3_CLAMP_LAMP 3 "No_difinition" 2 "LAMP_BLINK" 1 "LAMP_ON" 0 "LAMP_OFF" ;
VAL_ 811 EPB32B_4_5_WARN_LAMP 3 "No_difinition" 2 "LAMP_BLINK" 1 "LAMP_ON" 0 "LAMP_OFF" ;
VAL_ 811 EPB32B_4_7_WARN_EPB_MET_LCD 1 "INDICATE" 0 "NOT_IINDICATE" ;
VAL_ 811 EPB32B_3_0_STATUS_EPB 7 "No_difinition" 6 "No_difinition" 5 "DYNAMIC PARKING" 4 "RELEASING" 3 "OPERATING" 2 "OPERATE" 1 "RELEASE" 0 "ERROR" ;
VAL_ 811 EPB32B_3_3_DYNAMIC_PARKING 1 "ON" 0 "OFF" ;
VAL_ 811 EPB32B_3_4_HILL_HOLD_RUN_FLG 1 "OPERATE" 0 "NOT_OPERATE" ;
VAL_ 811 EPB32B_3_5_INHIBIT_ISS_DELAY 1 "INHIBIT" 0 "PERMIT" ;
VAL_ 811 EPB32B_3_6_INHIBIT_ISS 1 "INHIBIT" 0 "PERMIT" ;
VAL_ 811 EPB32B_3_7_AVH_PERMIT_CONT_ACC 1 "PERMISSION" 0 "PROHIBITION" ;
VAL_ 811 EPB32B_2_0_ERR_INFO 3 "PULL_FORCE_FAIL" 2 "EMERGENCY_RELEASE" 1 "STROKE_SHORT" 0 "NORMAL" ;
VAL_ 811 EPB32B_2_2_EPB_FAIL_FLG1 1 "PERMIT" 0 "INHIBIT" ;
VAL_ 811 EPB32B_2_3_EPB_FAIL_FLG2 1 "PERMIT" 0 "INHIBIT" ;
VAL_ 811 EPB32B_2_4_EPB_FAIL_FLG3 1 "PERMIT" 0 "INHIBIT" ;
VAL_ 811 EPB32B_1_4_WAKE_UP_FRAME 1 "WakeUP_FRAME" 0 "Normal_FRAME" ;
VAL_ 811 EPB32B_1_5_REQ_COMM_CONT 1 "REQUEST" 0 "NO_REQUEST" ;
VAL_ 323 VDC143_1_4_IG_ON 0 "OFF" 1 "ON" ;
VAL_ 323 VDC143_1_5_VEHICLE_SPEED_Q 3 "Reserved" 2 "Faulty" 1 "Normal" 0 "NotInitialized" ;
VAL_ 323 VDC143_1_7_DIAG_STATUS 0 "NON DIAG MODE" 1 "DIAG MODE" ;
VAL_ 362 VDC16A_3_7_JUDGE_EXTRUSION 1 "EXTRUSION" 0 "OTHER" ;
VAL_ 316 VDC13C_7_0_RCV_FAIL_ADA 1 "ALIVE" 0 "NO_ALIVE" ;
VAL_ 316 VDC13C_7_1_FAIL_PCU 1 "NORMAL" 0 "FAIL" ;
VAL_ 316 VDC13C_7_2_CONT_STATE_ES_BRAKE 1 "ALIVE" 0 "NO_ALIVE" ;
VAL_ 316 VDC13C_7_3_ASST_PRECRUSH_ACC 1 "ACTIVE" 0 "NON_ACTIVE" ;
VAL_ 316 VDC13C_7_4_CONT_STATE_PRECRUSH 1 "ACTIVE" 0 "NON_ACTIVE" ;
VAL_ 316 VDC13C_7_5_PERMIT_BRAKE_ACC 1 "PERMIT" 0 "INHIBIT" ;
VAL_ 316 VDC13C_7_6_DETECT_BRAKING 1 "Driver Brake_ON" 0 "Driver Brake_OFF" ;
VAL_ 316 VDC13C_7_7_EMERGENCY_BRAKE 1 "ON" 0 "OFF" ;
VAL_ 316 VDC13C_6_6_VDC_OFF 1 "SYS_ON" 0 "SYS_OFF" ;
VAL_ 316 VDC13C_6_7_STBY_PREVIEW_VDC 1 "PREVIEW_VDC" 0 "NORMAL_VDC" ;
VAL_ 316 VDC13C_5_7_ACTIVATE_TSM 1 "CONTROL" 0 "NOT_CONTROL" ;
VAL_ 316 VDC13C_4_7_ACTIVATE_RMI 1 "CONTROL" 0 "NOT_CONTROL" ;
VAL_ 316 VDC13C_3_7_ACTIVATE_VECTARING 1 "ACTIVE" 0 "NON_ACTIVE" ;
VAL_ 316 VDC13C_2_7_STATE_ACTIVATE_HSA 1 "ACTIVE" 0 "NON_ACTIVE" ;
VAL_ 316 VDC13C_1_4_ACTIVE_BRAKEHOLD 1 "HOLD" 0 "RELEASE" ;
VAL_ 316 VDC13C_1_5_PROHIBIT_BRAKEHOLD 1 "PROHIBIT" 0 "PERMIT" ;
VAL_ 316 VDC13C_1_6_BRAKELAMP_RELAY 1 "ON" 0 "OFF" ;
VAL_ 316 VDC13C_1_7_STATUS_BRAKELAMP 1 "W/C>0MPa_and_ID160_B2b4=1" 0 "TURN_OFF" ;
VAL_ 315 VDC13B_1_4_BRAKE_TYPE 1 "ACTIVE_BOOSTER" 0 "VDC" ;
VAL_ 315 VDC13B_1_5_REQ_ENG_TRQ_DOWN 1 "REQ" 0 "NON_REQ" ;
VAL_ 315 VDC13B_1_6_REQ_ENG_TRQ_UP 1 "REQ" 0 "NON_REQ" ;
VAL_ 315 VDC13B_1_7_PROHIBIT_FUEL_CUT 1 "PROHIBIT" 0 "PERMIT" ;
VAL_ 313 VDC139_7_4_FAIL_PRESSURE_SSR 1 "NORMAL" 0 "FAIL" ;
VAL_ 313 VDC139_7_5_STATUS_EPB 7 "No_difinition" 6 "AVH_OPERATE" 5 "DYNAMIC PARKING" 4 "RELEASING" 3 "OPERATING" 2 "OPERATE" 1 "RELEASE" 0 "ERROR" ;
VAL_ 313 VDC139_4_0_HDC_STATUS 3 "Uncertain(SYS_OFF)" 2 "SYS_ACTIVE" 1 "SYS_WAIT" 0 "SYS_OFF" ;
VAL_ 313 VDC139_4_2_BRAKELAMPSW 1 "ON" 0 "OFF" ;
VAL_ 313 VDC139_4_3_FAIL_BRAKELAMPSW 1 "NORMAL" 0 "FAIL" ;
VAL_ 313 VDC139_4_4_ACTIVATE_ABS 1 "ACTIVE" 0 "NON_ACTIVE" ;
VAL_ 313 VDC139_4_5_ACTIVATE_TCS 1 "ACTIVE" 0 "NON_ACTIVE" ;
VAL_ 313 VDC139_4_6_CONT_OVER_STR 1 "control" 0 "NON_Control" ;
VAL_ 313 VDC139_4_7_CONT_UNDER_STR 1 "control" 0 "NON_Control" ;
VAL_ 313 VDC139_3_5_FAIL_VDC_SSR 1 "NORMAL" 0 "FAIL" ;
VAL_ 313 VDC139_3_6_FAIL_SPD_SSR_FHI 1 "NORMAL" 0 "FAIL" ;
VAL_ 313 VDC139_3_7_FAIL_ABS_SYS 1 "NORMAL" 0 "FAIL" ;
VAL_ 313 VDC139_1_4_FAIL_HDC_SYS 1 "NORMAL" 0 "FAIL" ;
VAL_ 313 VDC139_1_5_VEHICLE_HIGHT 2 "STANDARD" 1 "OBK" 0 "NON" ;
VAL_ 313 VDC139_1_7_REPROGRAMING 1 "STOP_Diag&COMM" 0 "NORMAL" ;
VAL_ 312 VDC138_1_4_ACTIVE_LDP 1 "ACTIVE" 0 "NON_ACTIVE" ;
VAL_ 312 VDC138_1_5_PROHIBIT_LDP 1 "PROHIBIT" 0 "PERMIT" ;
VAL_ 312 VDC138_1_6_VDC_SMALL_MARGIN 1 "SMALL MARGIN" 0 "NOMAL" ;
VAL_ 312 VDC138_1_7_DETECT_REAR_SLIP 1 "CONTROL" 0 "NOT_CONTROL" ;
VAL_ 952 CCU3B8_6_0_ACPANEL_STEER_H_LINK 3 "" 2 "" 1 "SW Push Event" 0 "invalid" ;
VAL_ 952 CCU3B8_5_6_ACPANEL_SEAT_H_LINK_P 3 "" 2 "" 1 "SW Push Event" 0 "invalid" ;
VAL_ 952 CCU3B8_5_4_ACPANEL_SEAT_H_LINK_D 3 "" 2 "" 1 "SW Push Event" 0 "invalid" ;
VAL_ 952 CCU3B8_4_3_ACPANEL_SEAT_V_TEMP_P 3 "Not Operation" 2 "Mild" 1 "Strong" 0 "Normal" ;
VAL_ 952 CCU3B8_4_0_ACPANEL_SEAT_V_TEMP_D 3 "Not Operation" 2 "Mild" 1 "Strong" 0 "Normal" ;
VAL_ 952 CCU3B8_3_7_ACN_CSTM_REQ 1 "required" 0 "NOT_required" ;
VAL_ 952 CCU3B8_3_3_ACPANEL_SEAT_H_TEMP_P 3 "Not Operation" 2 "Mild" 1 "Strong" 0 "Normal" ;
VAL_ 952 CCU3B8_3_0_ACPANEL_SEAT_H_TEMP_D 3 "Not Operation" 2 "Mild" 1 "Strong" 0 "Normal" ;
VAL_ 952 CCU3B8_2_0_ACPANEL_FAN_ONLY_SW 3 "" 2 "" 1 "SW Push Event" 0 "invalid" ;
VAL_ 952 CCU3B8_2_1_ACPANEL_INNER_AIR 3 "Undefind" 2 "Outside Air" 1 "Recirculation" 0 "invalid" ;
VAL_ 952 CCU3B8_1_6_ACPANEL_AUTO_ECO_SW 3 "" 2 "" 1 "SW Push Event" 0 "invalid" ;
VAL_ 952 CCU3B8_1_4_STEER_HEAT_SW 3 "" 2 "" 1 "SW Push Event" 0 "invalid" ;
VAL_ 1710 CCU6AE_2_4_DEST_PRD_NUM 21 "Reserve" 20 "Reserve" 19 "Reserve" 18 "Reserve" 17 "Reserve" 16 "Reserve" 9 "Reserve" 8 "Reserve" 7 "Reserve" 6 "STANDARD" 5 "Europe" 4 "China" 3 "Australia" 2 "DOM" 1 "US_CANADA" 0 "Undefind" ;
VAL_ 1710 CCU6AE_2_2_VDC_SW_INFO 2 "ON_SW" 1 "OFF_SW" 0 "NOT_operation" ;
VAL_ 1710 CCU6AE_2_0_ISS_SW_INFO 1 "ON" 0 "OFF" ;
VAL_ 1707 CCU6AB_7_3_REQ_RESET_CSTM_TPM 1 "required" 0 "NOT required" ;
VAL_ 1707 CCU6AB_7_2_TPM_CSTM_CHG_REQ 1 "required" 0 "NOT required" ;
VAL_ 1707 CCU6AB_7_0_CSTM_TIRE_UNIT 1 "kPa" 0 "PSi" ;
VAL_ 1707 CCU6AB_6_3_REQ_RESET_CSTM_AHL 1 "required" 0 "NOT_required" ;
VAL_ 1707 CCU6AB_6_2_SRH_CSTM_CHG_REQ 1 "required" 0 "NOT_required" ;
VAL_ 1707 CCU6AB_6_0_SRH_CSTM_CHG_SET 1 "ON" 0 "OFF" ;
VAL_ 1707 CCU6AB_5_0_SEATAWAY_DST_CSTM 3 "Min" 2 "Mid" 1 "Max" 0 "NOT_required" ;
VAL_ 1707 CCU6AB_5_2_DRIVER_POSI_REQ 2 "Recovery" 1 "Save" 0 "NOT_required" ;
VAL_ 1707 CCU6AB_5_6_OCCUPANT_DETECT_REQ 3 "Reserve" 2 "Reserve" 1 "required" 0 "NOT required" ;
VAL_ 1707 CCU6AB_4_6_AFOLD_SW_MIR_SW 1 "required" 0 "NOT_required" ;
VAL_ 1707 CCU6AB_4_2_MIR_DIRECTION_MIR_SW 4 "Right" 3 "Left" 2 "Down" 1 "Up" 0 "NOT_required" ;
VAL_ 1707 CCU6AB_4_0_MIR_SELECT_LR_MIR_SW 2 "Right" 1 "Left" 0 "NOT_required" ;
VAL_ 1707 CCU6AB_3_0_PRG_OPENER_SW 1 "SW_Press" 0 "SW_NOT_Press" ;
VAL_ 1707 CCU6AB_3_1_PRG_MEM_CHG_REQ 1 "required" 0 "NOT_required" ;
VAL_ 1707 CCU6AB_3_2_PRG_HF_CHG_REQ 1 "required" 0 "NOT_required" ;
VAL_ 1707 CCU6AB_3_6_MIR_RTILT_R_CSTM 1 "required" 0 "NOT required" ;
VAL_ 1707 CCU6AB_3_7_MIR_RTILT_L_CSTM 1 "required" 0 "NOT required" ;
VAL_ 1707 CCU6AB_2_6_WASH_CAR_MODE_REQ 1 "required" 0 "NOT_required" ;
VAL_ 1707 CCU6AB_2_4_SHUT_DOWN_MODE_REQ 1 "required" 0 "NOT_required" ;
VAL_ 1707 CCU6AB_2_2_PET_MODE_SWITCH_REQ 1 "required" 0 "NOT_required" ;
VAL_ 1707 CCU6AB_2_0_POW_ON_FIX_MODE_REQ 1 "required" 0 "NOT_required" ;
VAL_ 1707 CCU6AB_1_7_CECU_CSTM_RESET_REQ 1 "required" 0 "NOT_required" ;
VAL_ 1706 CCU6AA_5_0_WINDOW_LOCK_SET_REQ 1 "required" 0 "NOT_required" ;
VAL_ 1706 CCU6AA_5_2_DOOR_LINK_SET_REQ 1 "required" 0 "NOT_required" ;
VAL_ 1706 CCU6AA_5_4_BULK_TURN_ON_REQ 1 "required" 0 "NOT_required" ;
VAL_ 1706 CCU6AA_5_6_WIPER_SERV_MODE_REQ 3 "Reserve" 2 "ON" 1 "OFF" 0 "NOT required" ;
VAL_ 1706 CCU6AA_4_0_ITMITT_SENSITIVE_REQ 21 "Reserve" 20 "Reserve" 19 "Reserve" 18 "Reserve" 17 "Reserve" 16 "Reserve" 9 "Reserve" 8 "Reserve" 7 "Reserve" 6 "Reserve" 5 "Reserve" 4 "4" 3 "3" 2 "2" 1 "1" 0 "NOT required" ;
VAL_ 1706 CCU6AA_4_4_REAR_WIPER_SET_REQ 3 "Hi" 2 "Lo" 1 "OFF" 0 "NOT_required" ;
VAL_ 1706 CCU6AA_3_0_WELCOME_RIDEON_REQ 7 "Reserve" 6 "Reserve" 5 "Reserve" 4 "30sec" 3 "20sec" 2 "10sec" 1 "OFF" 0 "NOT required" ;
VAL_ 1706 CCU6AA_3_3_WELCOME_GETOFF_REQ 7 "Reserve" 6 "90sec" 5 "60sec" 4 "30sec" 3 "20sec" 2 "10sec" 1 "OFF" 0 "NOT required" ;
VAL_ 1706 CCU6AA_2_0_WIPER_HEADLAMP_REQ 3 "Reserve" 2 "ON" 1 "OFF" 0 "NOT required" ;
VAL_ 1706 CCU6AA_1_4_WIUL_CUSTOM_REQ 2 "ON" 1 "OFF" 0 "NOT_required" ;
VAL_ 1706 CCU6AA_1_6_WAL_CUSTOM_REQ 2 "ON" 1 "OFF" 0 "NOT_required" ;
VAL_ 1704 CCU6A8_7_5_TRQ_CHG_MODE_SET 3 "Blink" 2 "ON" 1 "OFF" 0 "NOT_required" ;
VAL_ 1704 CCU6A8_7_3_ADAPT_DEC_CHG_REQ 3 "Blink" 2 "ON" 1 "OFF" 0 "NOT_required" ;
VAL_ 1704 CCU6A8_7_0_DEC_SELECT_REQ_B 3 "Hi" 2 "Mid" 1 "Lo" 0 "NOT_required" ;
VAL_ 1704 CCU6A8_6_5_DEC_SELECT_REQ_D 3 "Hi" 2 "Mid" 1 "Lo" 0 "NOT_required" ;
VAL_ 1704 CCU6A8_6_2_DEC_SELECT_REQ_ALL 3 "Hi" 2 "Mid" 1 "Lo" 0 "NOT_required" ;
VAL_ 1704 CCU6A8_6_0_DEC_SELECT_REQ_IND 3 "Blink" 2 "ON" 1 "OFF" 0 "NOT_required" ;
VAL_ 1704 CCU6A8_5_2_TOWING_MODE_REQ 2 "ON" 1 "OFF" 0 "NOT_required" ;
VAL_ 1704 CCU6A8_5_0_FACTORY_MODE_STATE 3 "Blink" 2 "ON" 1 "OFF" 0 "NOT_required" ;
VAL_ 1704 CCU6A8_4_2_TRIP_RESET_REQ 1 "required" 0 "NOT_required" ;
VAL_ 1704 CCU6A8_4_0_TRIP_SWITCH_REQ 3 "TRIP B" 2 "TRIP A" 1 "ODO" 0 "NOT required" ;
VAL_ 1704 CCU6A8_3_0_DOW_SFT_POS_SET 1 "required" 0 "NOT required" ;
VAL_ 1704 CCU6A8_2_6_DOW_SET 1 "required" 0 "NOT required" ;
VAL_ 1704 CCU6A8_2_4_RCTA_SET 1 "required" 0 "NOT required" ;
VAL_ 1704 CCU6A8_2_2_BSD_LCA_2ND_SET 1 "required" 0 "NOT required" ;
VAL_ 1704 CCU6A8_2_0_SRVD_SET 1 "required" 0 "NOT required" ;
VAL_ 1704 CCU6A8_1_6_RCR_CSTM_RESET_REQ 1 "required" 0 "NOT required" ;
VAL_ 1704 CCU6A8_1_4_BEV_CSTM_RESET_REQ 1 "required" 0 "NOT required" ;
VAL_ 1649 MCL671_3_4_MIR_SEN_H_ANOMALOUS 1 "Abnormal" 0 "Normal" ;
VAL_ 1649 MCL671_3_5_MIR_SEN_V_ANOMALOUS 1 "Abnormal" 0 "Normal" ;
VAL_ 1649 MCL671_2_0_NVM_ANOMALOUS 1 "Abnormal" 0 "Normal" ;
VAL_ 1649 MCL671_2_1_POWER_ANOMALOUS 1 "Abnormal" 0 "Normal" ;
VAL_ 1648 MCL670_4_0_STATE_ACT_HTR_LMR 3 "Reserved" 2 "Reserved" 1 "On" 0 "Off" ;
VAL_ 1648 MCL670_3_0_STATE_ACT_CTL_L 3 "Reserved" 2 "Reserved" 1 "On" 0 "Off" ;
VAL_ 1648 MCL670_2_0_MCL_APPLY_CONST 8 "Reserved" 7 "Definition7" 6 "Definition6" 5 "Definition5" 4 "Definition4" 3 "Definition3" 2 "Definition2" 1 "Definition1" 0 "No setting" ;
VAL_ 1647 MCL66F_3_0_STATE_ACT_MIR_LMR 4 "Right" 3 "Left" 2 "Down" 1 "Up" 0 "No request" ;
VAL_ 1647 MCL66F_2_0_CUR_POS_AFOLD_LMR 3 "Midway" 2 "Folding " 1 "Return" 0 "Undetermined" ;
VAL_ 1647 MCL66F_2_2_STATE_ACT_AFOLD_LMR 3 "Reserved" 2 "Mirrors returning" 1 "Mirrors folding" 0 "Stop" ;
VAL_ 1644 MCR66C_3_4_MIR_SEN_H_ANOMALOUS 1 "Abnormal" 0 "Normal" ;
VAL_ 1644 MCR66C_3_5_MIR_SEN_V_ANOMALOUS 1 "Abnormal" 0 "Normal" ;
VAL_ 1644 MCR66C_2_0_NVM_ANOMALOUS 1 "Abnormal" 0 "Normal" ;
VAL_ 1644 MCR66C_2_1_POWER_ANOMALOUS 1 "Abnormal" 0 "Normal" ;
VAL_ 1643 MCR66B_4_0_STATE_ACT_HTR_RMR 3 "Reserved" 2 "Reserved" 1 "On" 0 "Off" ;
VAL_ 1643 MCR66B_3_0_STATE_ACT_CTL_R 3 "Reserved" 2 "Reserved" 1 "On" 0 "Off" ;
VAL_ 1643 MCR66B_2_0_MCR_APPLY_CONST 8 "Reserved" 7 "Definition7" 6 "Definition6" 5 "Definition5" 4 "Definition4" 3 "Definition3" 2 "Definition2" 1 "Definition1" 0 "No setting" ;
VAL_ 1642 MCR66A_3_0_STATE_ACT_MIR_RMR 4 "Right" 3 "Left" 2 "Down" 1 "Up" 0 "No request" ;
VAL_ 1642 MCR66A_2_0_CUR_POS_AFOLD_RMR 3 "Midway" 2 "Folding " 1 "Return" 0 "Undetermined" ;
VAL_ 1642 MCR66A_2_2_STATE_ACT_AFOLD_RMR 3 "Reserved" 2 "Mirrors returning" 1 "Mirrors folding" 0 "Stop" ;
VAL_ 1610 SMT64A_0_0_RGMDDK1 40 "Pattern4" 34 "Pattern3" 33 "Pattern2" 0 "Pattern1" ;
VAL_ 1605 SMT645_3_0_RQID2ME 3 "BLE/UWB/NFC" 2 "NFC" 1 "BLE/UWB" 0 "No set" ;
VAL_ 1605 SMT645_3_4_RQID2ID 15 "NFC4" 14 "NFC3" 13 "NFC2" 12 "NFC1" 11 "NFC" 7 "Key7" 6 "Key6" 5 "Key5" 4 "Key4" 3 "Key3" 2 "Key2" 1 "Key1" 0 "No Specify" ;
VAL_ 1605 SMT645_2_0_RQID2AR 11 "Pattern10" 10 "Pattern9" 9 "Pattern8" 8 "Pattern7" 7 "Pattern6" 6 "Pattern5" 3 "Pattern4" 2 "Pattern3" 1 "Pattern2" 0 "Pattern1" ;
VAL_ 1605 SMT645_2_4_RQID1ME 3 "BLE/UWB/NFC" 2 "NFC" 1 "BLE/UWB" 0 "No set" ;
VAL_ 1605 SMT645_1_0_RQID1ID 15 "NFC4" 14 "NFC3" 13 "NFC2" 12 "NFC1" 11 "NFC" 7 "Key7" 6 "Key6" 5 "Key5" 4 "Key4" 3 "Key3" 2 "Key2" 1 "Key1" 0 "No Specify" ;
VAL_ 1605 SMT645_1_4_RQID1AR 11 "Pattern10" 10 "Pattern9" 9 "Pattern8" 8 "Pattern7" 7 "Pattern6" 6 "Pattern5" 3 "Pattern4" 2 "Pattern3" 1 "Pattern2" 0 "Pattern1" ;
VAL_ 1605 SMT645_0_0_RQINF 3 "Near/Far" 2 "Far" 1 "Near" 0 "No reqest" ;
VAL_ 1605 SMT645_0_2_RQIDCNT 3 "Count3" 2 "Count2" 1 "Count1" 0 "Count0" ;
VAL_ 1605 SMT645_0_4_RQIDDEVI 2 "DKY" ;
VAL_ 1604 SMT644_6_0_RSPRECK 5 "Pattern6" 4 "Pattern5" 3 "Pattern4" 2 "Pattern3" 1 "Pattern2" 0 "Pattern1" ;
VAL_ 1604 SMT644_5_0_SPMODEID 4 "Unique" 3 "Register" 0 "Normal" ;
VAL_ 1604 SMT644_3_4_NUM_NFCCARD 4 "Num4" 3 "Num3" 2 "Num2" 1 "Num1" 0 "Num0" ;
VAL_ 1604 SMT644_2_0_RQISME 7 "Stop " 3 "BLE/UWB/NFC" 2 "NFC" 1 "BLE/UWB" 0 "No reqest" ;
VAL_ 1604 SMT644_2_4_RQISDEVI 2 "DKY" ;
VAL_ 1313 DKY521_1_4_ActiveWakeUpBit 1 "active wakeup" 0 "passive wakeup" ;
VAL_ 1613 DKY64D_0_5_BLEMSGID 5 "Pattern5" 4 "Pattern4" 3 "Pattern3" 2 "Pattern2" 1 "Pattern1" ;
VAL_ 1612 DKY64C_5_6_DKY_RSLT 3 "Pattern4" 2 "Pattern3" 1 "Pattern2" 0 "Pattern１" ;
VAL_ 1612 DKY64C_4_0_RSRGDK 54 "Pattern15" 53 "Pattern14" 52 "Pattern13" 51 "Pattern12" 50 "Pattern11" 49 "Pattern10" 40 "Pattern9" 39 "Pattern8" 38 "Pattern7" 37 "Pattern6" 36 "Pattern5" 35 "Pattern4" 34 "Pattern3" 17 "Pattern2" 0 "Pattern1" ;
VAL_ 1612 DKY64C_0_0_DKRGNGFC 132 "Pattern11" 131 "Pattern10" 130 "Pattern9" 129 "Pattern8" 128 "Pattern7" 5 "Pattern6" 4 "Pattern5" 3 "Pattern4" 2 "Pattern3" 1 "Pattern2" 0 "Pattern1" ;
VAL_ 1609 DKY649_3_0_TMIDH 7 "Key7" 6 "Key6" 5 "Key5" 4 "Key4" 3 "Key3" 2 "Key2" 1 "Key1" 0 "Other Key/NFC" ;
VAL_ 1609 DKY649_3_3_WCNTH 3 "Count3" 2 "Count2" 1 "Count1" 0 "Count0" ;
VAL_ 1609 DKY649_2_0_HWOPE2 192 "stop" 168 "100% open" 128 "open" 64 "close" 0 "no request" ;
VAL_ 1609 DKY649_1_0_HWOPE1 2 "stop" 1 "start" 0 "no request" 4 "trunk" 8 "PRG" ;
VAL_ 1609 DKY649_1_4_HWLOC 7 "Pattern2" 2 "Pattern1" 0 "ini" ;
VAL_ 1609 DKY649_0_4_KTYPEH 2 "DKYBLE" ;
VAL_ 1608 DKY648_3_0_TMIDD 7 "Key7" 6 "Key6" 5 "Key5" 4 "Key4" 3 "Key3" 2 "Key2" 1 "Key1" 0 "Other" ;
VAL_ 1608 DKY648_1_1_WINFD 32 "UNLOCK" 16 "LOCK" 0 "OFF" ;
VAL_ 1608 DKY648_0_4_KTYPED 14 "otherwise未定義" 4 "Pattern2" 3 "Pattern1" ;
VAL_ 1607 DKY647_2_5_DKSEN1ME 3 "Pattern4" 2 "Pattern3" 1 "Pattern2" 0 "Pattern1" ;
VAL_ 1607 DKY647_1_2_DKSEN1ID 15 "ＮＦＣカード4照合ＯＫ" 14 "ＮＦＣカード3照合ＯＫ" 13 "ＮＦＣカード2照合ＯＫ" 12 "ＮＦＣカード1照合ＯＫ" 11 "キーＩＤ１～７以外照合ＯＫ" 7 "キーＩＤ７照合ＯＫ" 6 "キーＩＤ６照合ＯＫ" 5 "キーＩＤ５照合ＯＫ" 4 "キーＩＤ４照合ＯＫ" 3 "キーＩＤ３照合ＯＫ" 2 "キーＩＤ２照合ＯＫ" 1 "キーＩＤ１照合ＯＫ" 0 "対象ＩＤ無し" ;
VAL_ 1607 DKY647_1_6_DKSEN1AR2 3 "Pattern3,7" 2 "Pattern2,6,10" 1 "Pattern1,5,9" 0 "Pattern0,4,8" ;
VAL_ 1607 DKY647_0_0_DKSEN1AR1 14 "otherwisereserved" 2 "Pattern8-10" 1 "Pattern4-7" 0 "Pattern0-3" ;
VAL_ 1607 DKY647_0_2_DKSENUNL 14 "otherwisereserved" 1 "ON" 0 "INI" ;
VAL_ 1607 DKY647_0_4_DKSENLOC 14 "otherwisereserved" 1 "ON" 0 "INI" ;
VAL_ 1575 DKY627_0_5_SPNUM 4 "Num4" 3 "Num3" 2 "Num2" 1 "Num1" 0 "No Connect" ;
VAL_ 1574 DKY626_2_5_PS_OPSTD 6 "Pattern5" 5 "Pattern4" 4 "Pattern3" 2 "Pattern2" 0 "Pattern1" ;
VAL_ 1573 DKY625_0_6_DK_REGST 3 "Pattern4" 2 "Pattern3" 1 "Pattern2" 0 "Pattern1" ;
VAL_ 1571 DKY623_1_3_SPMDEDK 6 "Pattern5" 4 "Pattern4" 3 "Pattern3" 2 "Pattern2" 0 "Pattern1" ;
VAL_ 1571 DKY623_0_2_DKINDCST 1 "ON" 0 "OFF" ;
VAL_ 1571 DKY623_0_4_BZRQ_DK 1 "Pattern2" 0 "Pattern1" ;
VAL_ 1556 DKY614_3_0_RSDK2ME 3 "BLE/UWB/NFC" 2 "NFC" 1 "BLE/UWB" 0 "No Verify" ;
VAL_ 1556 DKY614_2_1_RSDK2SAR 11 "Pattern10" 10 "Pattern9" 9 "Pattern8" 8 "Pattern7" 7 "Pattern6" 6 "Pattern5" 3 "Pattern4" 2 "Pattern3" 1 "Pattern2" 0 "Pattern1" ;
VAL_ 1556 DKY614_2_5_RSDK1ME 3 "BLE/UWB/NFC" 2 "NFC" 1 "BLE/UWB" 0 "No Verify" ;
VAL_ 1556 DKY614_1_2_RSDK1ID 15 "NFC4" 14 "NFC3" 13 "NFC2" 12 "NFC1" 11 "Other Key" 7 "Key7" 6 "Key6" 5 "Key5" 4 "Key4" 3 "Key3" 2 "Key２" 1 "Key1" 0 "No Verify" ;
VAL_ 1556 DKY614_0_2_RSDKNF 3 "Near Far" 2 "Far" 1 "Near" 0 "Default" ;
VAL_ 1556 DKY614_0_4_RSDKCNT 3 "Count3" 2 "Count2" 1 "Count1" 0 "Count0" ;
VAL_ 1556 DKY614_0_6_RSDKIDTS 3 "Completion" 2 "Negative" 1 "Positive" 0 "Default" ;
VAL_ 1555 DKY613_3_2_OSDKFRID 15 "ID15" 14 "ID14" 13 "ID13" 12 "ID12" 11 "ID11" 10 "ID10" 9 "ID9" 8 "ID8" 7 "ID7" 6 "ID6" 5 "ID5" 4 "ID4" 3 "ID3" 2 "ID2" 1 "ID1" 0 "No Verify" ;
VAL_ 1555 DKY613_3_6_OSDKFRNF 1 "Pattern2" 0 "Pattern1" ;
VAL_ 1555 DKY_613_1_1_OSDKRRID 15 "ID15" 14 "ID14" 13 "ID13" 12 "ID12" 11 "ID11" 10 "ID10" 9 "ID9" 8 "ID8" 7 "ID7" 6 "ID6" 5 "ID5" 4 "ID4" 3 "ID3" 2 "ID2" 1 "ID1" 0 "No Verify" ;
VAL_ 1555 DKY613_1_5_OSKYRRNF 1 "Pattern2" 0 "Pattern1" ;
VAL_ 1555 DKY613_0_2_OSDKPNF 1 "Pattern2" 0 "Pattern1" ;
VAL_ 1555 DKY613_0_3_OSDKDID 15 "ID15" 14 "ID14" 13 "ID13" 12 "ID12" 11 "ID11" 10 "ID10" 9 "ID9" 8 "ID8" 7 "ID7" 6 "ID6" 5 "ID5" 4 "ID4" 3 "ID3" 2 "ID2" 1 "ID1" 0 "No Verify" ;
VAL_ 1555 DKY613_0_7_OSDKDNF 1 "Pattern2" 0 "Pattern1" ;
VAL_ 1554 DKY612_0_1_RSISDDK 20 "NFC4" 19 "NFC3" 18 "NFC2" 17 "NFC1" 15 "KEY15" 14 "KEY14" 13 "KEY13" 12 "KEY12" 11 "KEY11" 10 "KEY10" 9 "KEY9" 8 "KEY8" 7 "KEY7" 6 "KEY6" 5 "KEY5" 4 "KEY4" 3 "KEY3" 2 "KEY2" 1 "KEY1" 0 "No Verify" ;
VAL_ 1554 DKY612_0_6_RSISDKME 3 "Pattern4" 2 "Pattern3" 1 "Pattern2" 0 "Pattern1" ;
